VERSION ""

NS_ :

BS_:

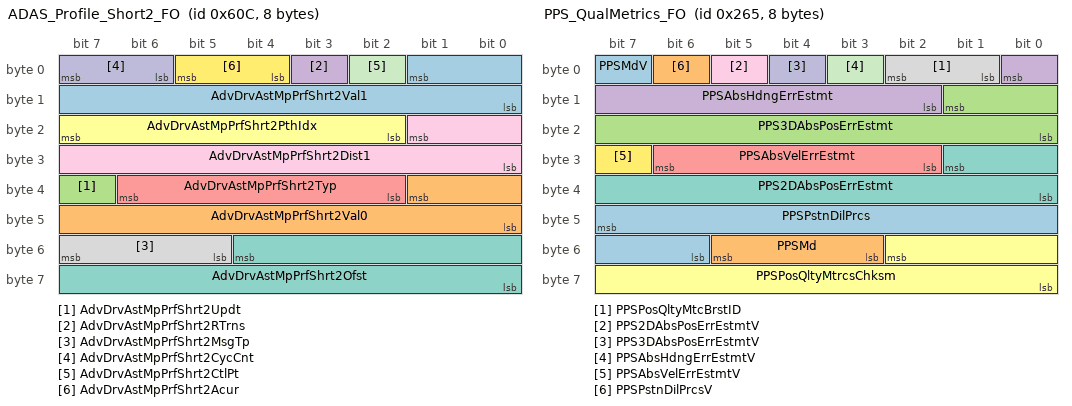
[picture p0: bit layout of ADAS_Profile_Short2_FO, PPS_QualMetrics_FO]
BO_ 1548 ADAS_Profile_Short2_FO: 8 AMM_FO
 SG_ AdvDrvAstMpPrfShrt2Val1 : 1|10@0+ (1,0) [0|1023] ""  EOCM2A_IMX6_FO,EOCM2A_K2_FO,EOCM2A_K1_FO,EOCM2B_IMX6_FO,EOCM2B_K2_FO,EOCM2B_K1_FO
 SG_ AdvDrvAstMpPrfShrt2Val0 : 33|10@0+ (1,0) [0|1023] ""  EOCM2A_IMX6_FO,EOCM2A_K2_FO,EOCM2A_K1_FO,EOCM2B_IMX6_FO,EOCM2B_K2_FO,EOCM2B_K1_FO
 SG_ AdvDrvAstMpPrfShrt2Updt : 39|1@0+ (1,0) [0|1] ""  EOCM2A_IMX6_FO,EOCM2A_K2_FO,EOCM2A_K1_FO,EOCM2B_IMX6_FO,EOCM2B_K2_FO,EOCM2B_K1_FO
 SG_ AdvDrvAstMpPrfShrt2RTrns : 3|1@0+ (1,0) [0|1] ""  EOCM2A_IMX6_FO,EOCM2A_K2_FO,EOCM2A_K1_FO,EOCM2B_IMX6_FO,EOCM2B_K2_FO,EOCM2B_K1_FO
 SG_ AdvDrvAstMpPrfShrt2Typ : 38|5@0+ (1,0) [0|31] ""  EOCM2A_IMX6_FO,EOCM2A_K2_FO,EOCM2A_K1_FO,EOCM2B_IMX6_FO,EOCM2B_K2_FO,EOCM2B_K1_FO
 SG_ AdvDrvAstMpPrfShrt2PthIdx : 23|6@0+ (1,0) [0|63] ""  EOCM2A_IMX6_FO,EOCM2A_K2_FO,EOCM2A_K1_FO,EOCM2B_IMX6_FO,EOCM2B_K2_FO,EOCM2B_K1_FO
 SG_ AdvDrvAstMpPrfShrt2Ofst : 52|13@0+ (1,0) [0|8191] "m"  EOCM2A_IMX6_FO,EOCM2A_K2_FO,EOCM2A_K1_FO,EOCM2B_IMX6_FO,EOCM2B_K2_FO,EOCM2B_K1_FO
 SG_ AdvDrvAstMpPrfShrt2MsgTp : 55|3@0+ (1,0) [0|7] ""  EOCM2A_IMX6_FO,EOCM2A_K2_FO,EOCM2A_K1_FO,EOCM2B_IMX6_FO,EOCM2B_K2_FO,EOCM2B_K1_FO
 SG_ AdvDrvAstMpPrfShrt2Dist1 : 17|10@0+ (1,0) [0|1023] "m"  EOCM2A_IMX6_FO,EOCM2A_K2_FO,EOCM2A_K1_FO,EOCM2B_IMX6_FO,EOCM2B_K2_FO,EOCM2B_K1_FO
 SG_ AdvDrvAstMpPrfShrt2CycCnt : 7|2@0+ (1,0) [0|3] ""  EOCM2A_IMX6_FO,EOCM2A_K2_FO,EOCM2A_K1_FO,EOCM2B_IMX6_FO,EOCM2B_K2_FO,EOCM2B_K1_FO
 SG_ AdvDrvAstMpPrfShrt2CtlPt : 2|1@0+ (1,0) [0|1] ""  EOCM2A_IMX6_FO,EOCM2A_K2_FO,EOCM2A_K1_FO,EOCM2B_IMX6_FO,EOCM2B_K2_FO,EOCM2B_K1_FO
 SG_ AdvDrvAstMpPrfShrt2Acur : 5|2@0+ (1,0) [0|3] ""  EOCM2A_IMX6_FO,EOCM2A_K2_FO,EOCM2A_K1_FO,EOCM2B_IMX6_FO,EOCM2B_K2_FO,EOCM2B_K1_FO

BO_ 1547 ADAS_Profile_Long2_FO: 8 AMM_FO
 SG_ AdvDrAstMpProfLng2Val : 39|32@0+ (1,0) [0|4294967295] ""  EOCM2A_IMX6_FO,EOCM2A_K2_FO,EOCM2A_K1_FO,EOCM2B_IMX6_FO,EOCM2B_K2_FO,EOCM2B_K1_FO
 SG_ AdvDrAstMpPrfLng2Updt : 7|1@0+ (1,0) [0|1] ""  EOCM2A_IMX6_FO,EOCM2A_K2_FO,EOCM2A_K1_FO,EOCM2B_IMX6_FO,EOCM2B_K2_FO,EOCM2B_K1_FO
 SG_ AdvDrAstMpPrfLng2RTrns : 6|1@0+ (1,0) [0|1] ""  EOCM2A_IMX6_FO,EOCM2A_K2_FO,EOCM2A_K1_FO,EOCM2B_IMX6_FO,EOCM2B_K2_FO,EOCM2B_K1_FO
 SG_ AdvDrAstMpPrfLng2PrfTyp : 4|5@0+ (1,0) [0|31] ""  EOCM2A_IMX6_FO,EOCM2A_K2_FO,EOCM2A_K1_FO,EOCM2B_IMX6_FO,EOCM2B_K2_FO,EOCM2B_K1_FO
 SG_ AdvDrAstMpPrfLng2PthIdx : 13|6@0+ (1,0) [0|63] ""  EOCM2A_IMX6_FO,EOCM2A_K2_FO,EOCM2A_K1_FO,EOCM2B_IMX6_FO,EOCM2B_K2_FO,EOCM2B_K1_FO
 SG_ AdvDrAstMpPrfLng2Ofst : 20|13@0+ (1,0) [0|8191] "m"  EOCM2A_IMX6_FO,EOCM2A_K2_FO,EOCM2A_K1_FO,EOCM2B_IMX6_FO,EOCM2B_K2_FO,EOCM2B_K1_FO
 SG_ AdvDrAstMpPrfLng2MgTyp : 23|3@0+ (1,0) [0|7] ""  EOCM2A_IMX6_FO,EOCM2A_K2_FO,EOCM2A_K1_FO,EOCM2B_IMX6_FO,EOCM2B_K2_FO,EOCM2B_K1_FO
 SG_ AdvDrAstMpPrfLng2CycCt : 15|2@0+ (1,0) [0|3] ""  EOCM2A_IMX6_FO,EOCM2A_K2_FO,EOCM2A_K1_FO,EOCM2B_IMX6_FO,EOCM2B_K2_FO,EOCM2B_K1_FO
 SG_ AdvDrAstMpPrfLng2CtrlPt : 5|1@0+ (1,0) [0|1] ""  EOCM2A_IMX6_FO,EOCM2A_K2_FO,EOCM2A_K1_FO,EOCM2B_IMX6_FO,EOCM2B_K2_FO,EOCM2B_K1_FO

BO_ 1630 USDT_Resp_From_EOCM2B_K2_FO: 8 EOCM2B_K2_FO
 SG_ DgnInf : 7|64@0+ (1,0) [0|1.84467440737096E+019] ""  TestTool_FO

BO_ 1374 UUDT_Resp_From_EOCM2B_K2_FO: 8 EOCM2B_K2_FO
 SG_ DgnInf : 7|64@0+ (1,0) [0|1.84467440737096E+019] ""  TestTool_FO

BO_ 606 USDT_Req_to_EOCM2B_K2_FO: 8 TestTool_FO
 SG_ DgnInf : 7|64@0+ (1,0) [0|1.84467440737096E+019] ""  EOCM2B_K2_FO

BO_ 328 Vehicle_Info_FO: 5 EOCM2A_K1_FO
 SG_ StrWhAngGrd : 27|12@0- (1,0) [-2048|2047] "deg/sec"  DMS_FO
 SG_ TrnsShftLvrPos : 31|4@0+ (1,0) [0|15] ""  DMS_FO
 SG_ StrWhAng_148 : 15|16@0- (0.0625,0) [-2048|2047.9375] "deg"  DMS_FO
 SG_ TrnsShftLvrPosV : 3|1@0+ (1,0) [0|1] ""  DMS_FO
 SG_ StrWhAngV_148 : 4|1@0+ (1,0) [0|1] ""  DMS_FO
 SG_ StrWhAngMsk_148 : 5|1@0+ (1,0) [0|1] ""  DMS_FO
 SG_ StrWhAngGrdV : 6|1@0+ (1,0) [0|1] ""  DMS_FO
 SG_ StrWhAngGrdMsk : 7|1@0+ (1,0) [0|1] ""  DMS_FO

BO_ 1930 DTC_Triggered_78A_FO: 7 LRSRR_FO
 SG_ DTCI_CodeSupported_78A : 40|1@0+ (1,0) [0|1] ""  TestTool_FO
 SG_ DTCI_CurrentStatus_78A : 41|1@0+ (1,0) [0|1] ""  TestTool_FO
 SG_ DTCI_DTCFailType_78A : 39|8@0+ (1,0) [0|255] ""  TestTool_FO
 SG_ DTCI_DTCFaultType_78A : 55|8@0+ (1,0) [0|255] ""  TestTool_FO
 SG_ DTCI_DTCNumber_78A : 23|16@0+ (1,0) [0|65535] ""  TestTool_FO
 SG_ DTCI_DTCSource_78A : 15|8@0+ (1,0) [0|255] ""  TestTool_FO
 SG_ DTCI_DTCTriggered_78A : 0|1@0+ (1,0) [0|1] ""  TestTool_FO
 SG_ DTCI_HistStat_78A : 44|1@0+ (1,0) [0|1] ""  TestTool_FO
 SG_ DTCI_TstFldCdClrdStat_78A : 43|1@0+ (1,0) [0|1] ""  TestTool_FO
 SG_ DTCI_TstFldPwrUpSt_78A : 46|1@0+ (1,0) [0|1] ""  TestTool_FO
 SG_ DTCI_TstNPsdCdClrdSt_78A : 42|1@0+ (1,0) [0|1] ""  TestTool_FO
 SG_ DTCI_TstNPsdPwrUpSt_78A : 45|1@0+ (1,0) [0|1] ""  TestTool_FO
 SG_ DTCIUnused1_78A : 7|1@0+ (1,0) [0|1] ""  TestTool_FO
 SG_ DTCIUnused2_78A : 6|1@0+ (1,0) [0|1] ""  TestTool_FO
 SG_ DTCIUnused3_78A : 5|1@0+ (1,0) [0|1] ""  TestTool_FO
 SG_ DTCIUnused4_78A : 4|1@0+ (1,0) [0|1] ""  TestTool_FO
 SG_ DTCIUnused5_78A : 3|1@0+ (1,0) [0|1] ""  TestTool_FO
 SG_ DTCIUnused6_78A : 2|1@0+ (1,0) [0|1] ""  TestTool_FO
 SG_ DTCIUnused7_78A : 1|1@0+ (1,0) [0|1] ""  TestTool_FO
 SG_ DTCI_WrnIndRqdSt_78A : 47|1@0+ (1,0) [0|1] ""  TestTool_FO

BO_ 1624 USDT_Resp_From_LRSRR: 8 LRSRR_FO
 SG_ DgnInf : 7|64@0+ (1,0) [0|1.84467440737096E+019] ""  TestTool_FO

BO_ 1368 UUDT_Resp_From_LRSRR: 8 LRSRR_FO
 SG_ DgnInf : 7|64@0+ (1,0) [0|1.84467440737096E+019] ""  TestTool_FO

BO_ 600 USDT_Req_to_LRSRR: 8 TestTool_FO
 SG_ DgnInf : 7|64@0+ (1,0) [0|1.84467440737096E+019] ""  LRSRR_FO

BO_ 613 PPS_QualMetrics_FO: 8 EOCM2A_K1_FO
 SG_ PPSPstnDilPrcs : 47|10@0+ (0.1,0) [0|102.3] ""  EOCM2B_IMX6_FO,EOCM2B_K2_FO,EOCM2B_K1_FO,AMM_FO
 SG_ PPSMd : 53|3@0+ (1,0) [0|7] ""  EOCM2B_IMX6_FO,EOCM2B_K2_FO,EOCM2B_K1_FO,AMM_FO
 SG_ PPS3DAbsPosErrEstmt : 9|10@0+ (0.1,0) [0|102.3] ""  EOCM2B_IMX6_FO,EOCM2B_K2_FO,EOCM2B_K1_FO,AMM_FO
 SG_ PPSAbsHdngErrEstmt : 0|7@0+ (0.5,0) [0|63.5] ""  EOCM2B_IMX6_FO,EOCM2B_K2_FO,EOCM2B_K1_FO,AMM_FO
 SG_ PPSAbsVelErrEstmt : 30|5@0+ (1,0) [0|31] ""  EOCM2B_IMX6_FO,EOCM2B_K2_FO,EOCM2B_K1_FO,AMM_FO
 SG_ PPSPosQltyMtrcsChksm : 50|11@0+ (1,0) [0|2047] ""  EOCM2B_IMX6_FO,EOCM2B_K2_FO,EOCM2B_K1_FO,AMM_FO
 SG_ PPS2DAbsPosErrEstmt : 25|10@0+ (0.1,0) [0|102.3] ""  EOCM2B_IMX6_FO,EOCM2B_K2_FO,EOCM2B_K1_FO,AMM_FO
 SG_ PPSPosQltyMtcBrstID : 2|2@0+ (1,0) [0|3] ""  EOCM2B_IMX6_FO,EOCM2B_K2_FO,EOCM2B_K1_FO,AMM_FO
 SG_ PPS2DAbsPosErrEstmtV : 5|1@0+ (1,0) [0|1] ""  EOCM2B_IMX6_FO,EOCM2B_K2_FO,EOCM2B_K1_FO,AMM_FO
 SG_ PPS3DAbsPosErrEstmtV : 4|1@0+ (1,0) [0|1] ""  EOCM2B_IMX6_FO,EOCM2B_K2_FO,EOCM2B_K1_FO,AMM_FO
 SG_ PPSAbsHdngErrEstmtV : 3|1@0+ (1,0) [0|1] ""  EOCM2B_IMX6_FO,EOCM2B_K2_FO,EOCM2B_K1_FO,AMM_FO
 SG_ PPSAbsVelErrEstmtV : 31|1@0+ (1,0) [0|1] ""  EOCM2B_IMX6_FO,EOCM2B_K2_FO,EOCM2B_K1_FO,AMM_FO
 SG_ PPSMdV : 7|1@0+ (1,0) [0|1] ""  EOCM2B_IMX6_FO,EOCM2B_K2_FO,EOCM2B_K1_FO,AMM_FO
 SG_ PPSPstnDilPrcsV : 6|1@0+ (1,0) [0|1] ""  EOCM2B_IMX6_FO,EOCM2B_K2_FO,EOCM2B_K1_FO,AMM_FO

BO_ 612 PPS_Time_FO: 8 EOCM2A_K1_FO
 SG_ PPSTmdayV : 2|1@0+ (1,0) [0|1] ""  EOCM2B_IMX6_FO,EOCM2B_K2_FO,EOCM2B_K1_FO,AMM_FO
 SG_ PPSCldrDayV : 0|1@0+ (1,0) [0|1] ""  EOCM2B_IMX6_FO,EOCM2B_K2_FO,EOCM2B_K1_FO,AMM_FO
 SG_ PPSCldrDay : 8|9@0+ (1,0) [0|511] ""  EOCM2B_IMX6_FO,EOCM2B_K2_FO,EOCM2B_K1_FO,AMM_FO
 SG_ PPSTmBrstID : 52|2@0+ (1,0) [0|3] ""  EOCM2B_IMX6_FO,EOCM2B_K2_FO,EOCM2B_K1_FO,AMM_FO
 SG_ PPSTmday : 31|27@0+ (1,0) [0|134217727] "ms"  EOCM2B_IMX6_FO,EOCM2B_K2_FO,EOCM2B_K1_FO,AMM_FO
 SG_ PPSTmChksm : 50|11@0+ (1,0) [0|2047] ""  EOCM2B_IMX6_FO,EOCM2B_K2_FO,EOCM2B_K1_FO,AMM_FO
 SG_ PPSCldrYrV : 1|1@0+ (1,0) [0|1] ""  EOCM2B_IMX6_FO,EOCM2B_K2_FO,EOCM2B_K1_FO,AMM_FO
 SG_ PPSCldrYr : 15|7@0+ (1,2014) [2014|2141] ""  EOCM2B_IMX6_FO,EOCM2B_K2_FO,EOCM2B_K1_FO,AMM_FO

BO_ 611 PPS_SigAcqTime_FO: 6 EOCM2A_K1_FO
 SG_ PPSSigAqTmBrstID : 38|2@0+ (1,0) [0|3] ""  EOCM2B_IMX6_FO,EOCM2B_K2_FO,EOCM2B_K1_FO,AMM_FO
 SG_ PPSSigAcqTmV : 39|1@0+ (1,0) [0|1] ""  EOCM2B_IMX6_FO,EOCM2B_K2_FO,EOCM2B_K1_FO,AMM_FO
 SG_ PPSSigAcqTm : 7|32@0+ (1,0) [0|4294967295] ""  EOCM2B_IMX6_FO,EOCM2B_K2_FO,EOCM2B_K1_FO,AMM_FO
 SG_ PPSSigAqTmChksm : 34|11@0+ (1,0) [0|2047] ""  EOCM2B_IMX6_FO,EOCM2B_K2_FO,EOCM2B_K1_FO,AMM_FO

BO_ 610 PPS_PosLong_FO: 6 EOCM2A_K1_FO
 SG_ PPSLongBrstID : 39|2@0+ (1,0) [0|3] ""  EOCM2B_IMX6_FO,EOCM2B_K2_FO,EOCM2B_K1_FO,AMM_FO
 SG_ PPSLong : 6|31@0- (1,0) [-1073741824|1073741823] ""  EOCM2B_IMX6_FO,EOCM2B_K2_FO,EOCM2B_K1_FO,AMM_FO
 SG_ PPSLongV : 7|1@0+ (1,0) [0|1] ""  EOCM2B_IMX6_FO,EOCM2B_K2_FO,EOCM2B_K1_FO,AMM_FO
 SG_ PPSLongChksm : 34|11@0+ (1,0) [0|2047] ""  EOCM2B_IMX6_FO,EOCM2B_K2_FO,EOCM2B_K1_FO,AMM_FO

BO_ 609 PPS_PosLat_FO: 6 EOCM2A_K1_FO
 SG_ PPSLatV : 7|1@0+ (1,0) [0|1] ""  EOCM2B_IMX6_FO,EOCM2B_K2_FO,EOCM2B_K1_FO,AMM_FO
 SG_ PPSLatChksm : 34|11@0+ (1,0) [0|2047] ""  EOCM2B_IMX6_FO,EOCM2B_K2_FO,EOCM2B_K1_FO,AMM_FO
 SG_ PPSLatBrstID : 36|2@0+ (1,0) [0|3] ""  EOCM2B_IMX6_FO,EOCM2B_K2_FO,EOCM2B_K1_FO,AMM_FO
 SG_ PPSLat : 5|30@0- (1,0) [-536870912|536870911] ""  EOCM2B_IMX6_FO,EOCM2B_K2_FO,EOCM2B_K1_FO,AMM_FO

BO_ 1160 PassPhrase_3_AMM_FO: 8 EOCM2A_K1_FO
 SG_ WiFiPssPhrsDgts17to24_Mp : 7|64@0+ (1,0) [0|0] ""  EOCM2B_K1_FO,AMM_FO

BO_ 1159 PassPhrase_2_AMM_FO: 8 EOCM2A_K1_FO
 SG_ WiFiPssPhrsDgts9to16_Mp : 7|64@0+ (1,0) [0|0] ""  EOCM2B_K1_FO,AMM_FO

BO_ 1158 PassPhrase_1_AMM_FO: 8 EOCM2A_K1_FO
 SG_ WiFiPssPhrsDgts1to8_Mp : 7|64@0+ (1,0) [0|0] ""  EOCM2B_K1_FO,AMM_FO

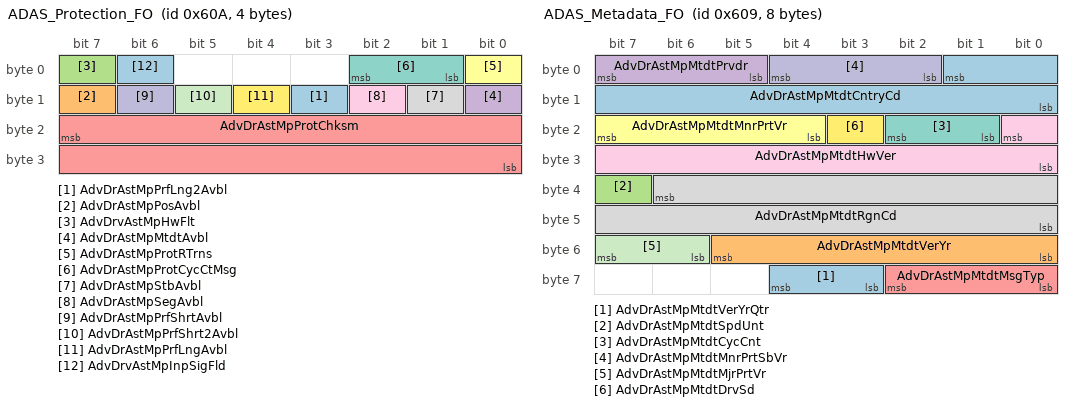
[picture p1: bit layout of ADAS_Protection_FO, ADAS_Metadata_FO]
BO_ 1546 ADAS_Protection_FO: 4 AMM_FO
 SG_ AdvDrAstMpPrfLng2Avbl : 11|1@0+ (1,0) [0|1] ""  EOCM2A_IMX6_FO,EOCM2A_K2_FO,EOCM2A_K1_FO,EOCM2B_IMX6_FO,EOCM2B_K2_FO,EOCM2B_K1_FO
 SG_ AdvDrAstMpPosAvbl : 15|1@0+ (1,0) [0|1] ""  EOCM2A_IMX6_FO,EOCM2A_K2_FO,EOCM2A_K1_FO,EOCM2B_IMX6_FO,EOCM2B_K2_FO,EOCM2B_K1_FO
 SG_ AdvDrvAstMpHwFlt : 7|1@0+ (1,0) [0|1] ""  EOCM2B_IMX6_FO,EOCM2B_K2_FO,EOCM2B_K1_FO,EOCM2A_IMX6_FO,EOCM2A_K2_FO,EOCM2A_K1_FO
 SG_ AdvDrAstMpMtdtAvbl : 8|1@0+ (1,0) [0|1] ""  EOCM2A_IMX6_FO,EOCM2A_K2_FO,EOCM2A_K1_FO,EOCM2B_IMX6_FO,EOCM2B_K2_FO,EOCM2B_K1_FO
 SG_ AdvDrAstMpProtChksm : 23|16@0+ (1,0) [0|65535] ""  EOCM2A_IMX6_FO,EOCM2A_K2_FO,EOCM2A_K1_FO,EOCM2B_IMX6_FO,EOCM2B_K2_FO,EOCM2B_K1_FO
 SG_ AdvDrAstMpProtRTrns : 0|1@0+ (1,0) [0|1] ""  EOCM2B_IMX6_FO,EOCM2B_K2_FO,EOCM2B_K1_FO,EOCM2A_IMX6_FO,EOCM2A_K2_FO,EOCM2A_K1_FO
 SG_ AdvDrAstMpProtCycCtMsg : 2|2@0+ (1,0) [0|3] ""  EOCM2B_IMX6_FO,EOCM2B_K2_FO,EOCM2B_K1_FO,EOCM2A_IMX6_FO,EOCM2A_K2_FO,EOCM2A_K1_FO
 SG_ AdvDrAstMpStbAvbl : 9|1@0+ (1,0) [0|1] ""  EOCM2A_IMX6_FO,EOCM2A_K2_FO,EOCM2A_K1_FO,EOCM2B_IMX6_FO,EOCM2B_K2_FO,EOCM2B_K1_FO
 SG_ AdvDrAstMpSegAvbl : 10|1@0+ (1,0) [0|1] ""  EOCM2A_IMX6_FO,EOCM2A_K2_FO,EOCM2A_K1_FO,EOCM2B_IMX6_FO,EOCM2B_K2_FO,EOCM2B_K1_FO
 SG_ AdvDrAstMpPrfShrtAvbl : 14|1@0+ (1,0) [0|1] ""  EOCM2A_IMX6_FO,EOCM2A_K2_FO,EOCM2A_K1_FO,EOCM2B_IMX6_FO,EOCM2B_K2_FO,EOCM2B_K1_FO
 SG_ AdvDrAstMpPrfShrt2Avbl : 13|1@0+ (1,0) [0|1] ""  EOCM2A_IMX6_FO,EOCM2A_K2_FO,EOCM2A_K1_FO,EOCM2B_IMX6_FO,EOCM2B_K2_FO,EOCM2B_K1_FO
 SG_ AdvDrAstMpPrfLngAvbl : 12|1@0+ (1,0) [0|1] ""  EOCM2A_IMX6_FO,EOCM2A_K2_FO,EOCM2A_K1_FO,EOCM2B_IMX6_FO,EOCM2B_K2_FO,EOCM2B_K1_FO
 SG_ AdvDrvAstMpInpSigFld : 6|1@0+ (1,0) [0|1] ""  EOCM2B_IMX6_FO,EOCM2B_K2_FO,EOCM2B_K1_FO,EOCM2A_IMX6_FO,EOCM2A_K2_FO,EOCM2A_K1_FO

BO_ 1545 ADAS_Metadata_FO: 8 AMM_FO
 SG_ AdvDrAstMpMtdtVerYrQtr : 60|2@0+ (1,1) [1|4] "Qtr"  EOCM2B_IMX6_FO,EOCM2B_K2_FO,EOCM2B_K1_FO,EOCM2A_IMX6_FO,EOCM2A_K2_FO,EOCM2A_K1_FO
 SG_ AdvDrAstMpMtdtVerYr : 53|6@0+ (1,2000) [2000|2063] "Year"  EOCM2B_IMX6_FO,EOCM2B_K2_FO,EOCM2B_K1_FO,EOCM2A_IMX6_FO,EOCM2A_K2_FO,EOCM2A_K1_FO
 SG_ AdvDrAstMpMtdtSpdUnt : 39|1@0+ (1,0) [0|1] ""  EOCM2B_IMX6_FO,EOCM2B_K2_FO,EOCM2B_K1_FO,EOCM2A_IMX6_FO,EOCM2A_K2_FO,EOCM2A_K1_FO
 SG_ AdvDrAstMpMtdtPrvdr : 7|3@0+ (1,0) [0|7] ""  EOCM2B_IMX6_FO,EOCM2B_K2_FO,EOCM2B_K1_FO,EOCM2A_IMX6_FO,EOCM2A_K2_FO,EOCM2A_K1_FO
 SG_ AdvDrAstMpMtdtMsgTyp : 58|3@0+ (1,0) [0|7] ""  EOCM2B_IMX6_FO,EOCM2B_K2_FO,EOCM2B_K1_FO,EOCM2A_IMX6_FO,EOCM2A_K2_FO,EOCM2A_K1_FO
 SG_ AdvDrAstMpMtdtMnrPrtVr : 23|4@0+ (1,0) [0|15] ""  EOCM2B_IMX6_FO,EOCM2B_K2_FO,EOCM2B_K1_FO,EOCM2A_IMX6_FO,EOCM2A_K2_FO,EOCM2A_K1_FO
 SG_ AdvDrAstMpMtdtCycCnt : 18|2@0+ (1,0) [0|3] ""  EOCM2B_IMX6_FO,EOCM2B_K2_FO,EOCM2B_K1_FO,EOCM2A_IMX6_FO,EOCM2A_K2_FO,EOCM2A_K1_FO
 SG_ AdvDrAstMpMtdtRgnCd : 38|15@0+ (1,0) [0|32767] ""  EOCM2B_IMX6_FO,EOCM2B_K2_FO,EOCM2B_K1_FO,EOCM2A_IMX6_FO,EOCM2A_K2_FO,EOCM2A_K1_FO
 SG_ AdvDrAstMpMtdtHwVer : 16|9@0+ (1,0) [0|511] ""  EOCM2B_IMX6_FO,EOCM2B_K2_FO,EOCM2B_K1_FO,EOCM2A_IMX6_FO,EOCM2A_K2_FO,EOCM2A_K1_FO
 SG_ AdvDrAstMpMtdtMnrPrtSbVr : 4|3@0+ (1,0) [0|7] ""  EOCM2B_IMX6_FO,EOCM2B_K2_FO,EOCM2B_K1_FO,EOCM2A_IMX6_FO,EOCM2A_K2_FO,EOCM2A_K1_FO
 SG_ AdvDrAstMpMtdtMjrPrtVr : 55|2@0+ (1,0) [0|3] ""  EOCM2B_IMX6_FO,EOCM2B_K2_FO,EOCM2B_K1_FO,EOCM2A_IMX6_FO,EOCM2A_K2_FO,EOCM2A_K1_FO
 SG_ AdvDrAstMpMtdtDrvSd : 19|1@0+ (1,0) [0|1] ""  EOCM2B_IMX6_FO,EOCM2B_K2_FO,EOCM2B_K1_FO,EOCM2A_IMX6_FO,EOCM2A_K2_FO,EOCM2A_K1_FO
 SG_ AdvDrAstMpMtdtCntryCd : 1|10@0+ (1,0) [0|1023] ""  EOCM2B_IMX6_FO,EOCM2B_K2_FO,EOCM2B_K1_FO,EOCM2A_IMX6_FO,EOCM2A_K2_FO,EOCM2A_K1_FO

BO_ 1543 ADAS_Profile_Long_FO: 8 AMM_FO
 SG_ AdvDrAstMpPrfLngUpdt : 7|1@0+ (1,0) [0|1] ""  EOCM2B_IMX6_FO,EOCM2B_K2_FO,EOCM2B_K1_FO,EOCM2A_IMX6_FO,EOCM2A_K2_FO,EOCM2A_K1_FO
 SG_ AdvDrAstMpPrfLngRTrns : 6|1@0+ (1,0) [0|1] ""  EOCM2B_IMX6_FO,EOCM2B_K2_FO,EOCM2B_K1_FO,EOCM2A_IMX6_FO,EOCM2A_K2_FO,EOCM2A_K1_FO
 SG_ AdvDrAstMpPrfLngCtlPt : 5|1@0+ (1,0) [0|1] ""  EOCM2B_IMX6_FO,EOCM2B_K2_FO,EOCM2B_K1_FO,EOCM2A_IMX6_FO,EOCM2A_K2_FO,EOCM2A_K1_FO
 SG_ AdvDrAstMpPrfLngTyp : 4|5@0+ (1,0) [0|31] ""  EOCM2B_IMX6_FO,EOCM2B_K2_FO,EOCM2B_K1_FO,EOCM2A_IMX6_FO,EOCM2A_K2_FO,EOCM2A_K1_FO
 SG_ AdvDrAstMpPrfLngCycCt : 15|2@0+ (1,0) [0|3] ""  EOCM2B_IMX6_FO,EOCM2B_K2_FO,EOCM2B_K1_FO,EOCM2A_IMX6_FO,EOCM2A_K2_FO,EOCM2A_K1_FO
 SG_ AdvDrAstMpPrfLngPthIdx : 13|6@0+ (1,0) [0|63] ""  EOCM2B_IMX6_FO,EOCM2B_K2_FO,EOCM2B_K1_FO,EOCM2A_IMX6_FO,EOCM2A_K2_FO,EOCM2A_K1_FO
 SG_ AdvDrAstMpPrfLngMsgTp : 23|3@0+ (1,0) [0|7] ""  EOCM2B_IMX6_FO,EOCM2B_K2_FO,EOCM2B_K1_FO,EOCM2A_IMX6_FO,EOCM2A_K2_FO,EOCM2A_K1_FO
 SG_ AdvDrAstMpPrfLngOfst : 20|13@0+ (1,0) [0|8191] "m"  EOCM2B_IMX6_FO,EOCM2B_K2_FO,EOCM2B_K1_FO,EOCM2A_IMX6_FO,EOCM2A_K2_FO,EOCM2A_K1_FO
 SG_ AdvDrAstMpPrfLngVal : 39|32@0+ (1,0) [0|4294967295] ""  EOCM2B_IMX6_FO,EOCM2B_K2_FO,EOCM2B_K1_FO,EOCM2A_IMX6_FO,EOCM2A_K2_FO,EOCM2A_K1_FO

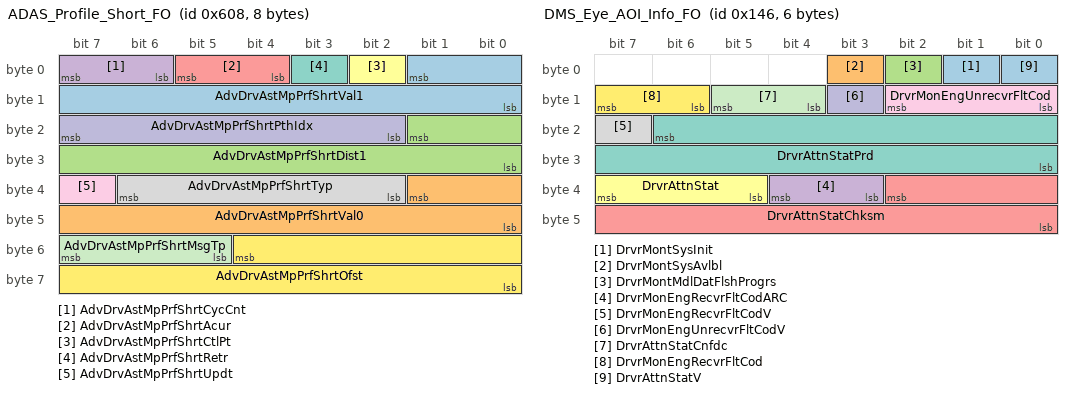
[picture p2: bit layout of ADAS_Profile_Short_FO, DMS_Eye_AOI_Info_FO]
BO_ 1544 ADAS_Profile_Short_FO: 8 AMM_FO
 SG_ AdvDrvAstMpPrfShrtVal1 : 1|10@0+ (1,0) [0|1023] ""  EOCM2B_IMX6_FO,EOCM2B_K2_FO,EOCM2B_K1_FO,EOCM2A_IMX6_FO,EOCM2A_K2_FO,EOCM2A_K1_FO
 SG_ AdvDrvAstMpPrfShrtVal0 : 33|10@0+ (1,0) [0|1023] ""  EOCM2B_IMX6_FO,EOCM2B_K2_FO,EOCM2B_K1_FO,EOCM2A_IMX6_FO,EOCM2A_K2_FO,EOCM2A_K1_FO
 SG_ AdvDrvAstMpPrfShrtDist1 : 17|10@0+ (1,0) [0|1023] "m"  EOCM2B_IMX6_FO,EOCM2B_K2_FO,EOCM2B_K1_FO,EOCM2A_IMX6_FO,EOCM2A_K2_FO,EOCM2A_K1_FO
 SG_ AdvDrvAstMpPrfShrtCycCnt : 7|2@0+ (1,0) [0|3] ""  EOCM2B_IMX6_FO,EOCM2B_K2_FO,EOCM2B_K1_FO,EOCM2A_IMX6_FO,EOCM2A_K2_FO,EOCM2A_K1_FO
 SG_ AdvDrvAstMpPrfShrtAcur : 5|2@0+ (1,0) [0|3] ""  EOCM2B_IMX6_FO,EOCM2B_K2_FO,EOCM2B_K1_FO,EOCM2A_IMX6_FO,EOCM2A_K2_FO,EOCM2A_K1_FO
 SG_ AdvDrvAstMpPrfShrtCtlPt : 2|1@0+ (1,0) [0|1] ""  EOCM2B_IMX6_FO,EOCM2B_K2_FO,EOCM2B_K1_FO,EOCM2A_IMX6_FO,EOCM2A_K2_FO,EOCM2A_K1_FO
 SG_ AdvDrvAstMpPrfShrtRetr : 3|1@0+ (1,0) [0|1] ""  EOCM2B_IMX6_FO,EOCM2B_K2_FO,EOCM2B_K1_FO,EOCM2A_IMX6_FO,EOCM2A_K2_FO,EOCM2A_K1_FO
 SG_ AdvDrvAstMpPrfShrtTyp : 38|5@0+ (1,0) [0|31] ""  EOCM2B_IMX6_FO,EOCM2B_K2_FO,EOCM2B_K1_FO,EOCM2A_IMX6_FO,EOCM2A_K2_FO,EOCM2A_K1_FO
 SG_ AdvDrvAstMpPrfShrtUpdt : 39|1@0+ (1,0) [0|1] ""  EOCM2B_IMX6_FO,EOCM2B_K2_FO,EOCM2B_K1_FO,EOCM2A_IMX6_FO,EOCM2A_K2_FO,EOCM2A_K1_FO
 SG_ AdvDrvAstMpPrfShrtPthIdx : 23|6@0+ (1,0) [0|63] ""  EOCM2B_IMX6_FO,EOCM2B_K2_FO,EOCM2B_K1_FO,EOCM2A_IMX6_FO,EOCM2A_K2_FO,EOCM2A_K1_FO
 SG_ AdvDrvAstMpPrfShrtMsgTp : 55|3@0+ (1,0) [0|7] ""  EOCM2B_IMX6_FO,EOCM2B_K2_FO,EOCM2B_K1_FO,EOCM2A_IMX6_FO,EOCM2A_K2_FO,EOCM2A_K1_FO
 SG_ AdvDrvAstMpPrfShrtOfst : 52|13@0+ (1,0) [0|8191] "m"  EOCM2B_IMX6_FO,EOCM2B_K2_FO,EOCM2B_K1_FO,EOCM2A_IMX6_FO,EOCM2A_K2_FO,EOCM2A_K1_FO

BO_ 1542 ADAS_Stub_FO: 8 AMM_FO
 SG_ AdvDrAstMpStbSubPthIdx : 63|6@0+ (1,0) [0|63] ""  EOCM2B_IMX6_FO,EOCM2B_K2_FO,EOCM2B_K1_FO,EOCM2A_IMX6_FO,EOCM2A_K2_FO,EOCM2A_K1_FO
 SG_ AdvDrAstMpStbUpdt : 55|1@0+ (1,0) [0|1] ""  EOCM2B_IMX6_FO,EOCM2B_K2_FO,EOCM2B_K1_FO,EOCM2A_IMX6_FO,EOCM2A_K2_FO,EOCM2A_K1_FO
 SG_ AdvDrAstMpStbPrtCalRut : 57|2@0+ (1,0) [0|3] ""  EOCM2B_IMX6_FO,EOCM2B_K2_FO,EOCM2B_K1_FO,EOCM2A_IMX6_FO,EOCM2A_K2_FO,EOCM2A_K1_FO
 SG_ AdvDrAstMpStbNmLnDrvDir : 54|3@0+ (1,0) [0|7] ""  EOCM2B_IMX6_FO,EOCM2B_K2_FO,EOCM2B_K1_FO,EOCM2A_IMX6_FO,EOCM2A_K2_FO,EOCM2A_K1_FO
 SG_ AdvDrAstMpStbCycCnt : 51|2@0+ (1,0) [0|3] ""  EOCM2B_IMX6_FO,EOCM2B_K2_FO,EOCM2B_K1_FO,EOCM2A_IMX6_FO,EOCM2A_K2_FO,EOCM2A_K1_FO
 SG_ AdvDrAstMpStbCmplxInsct : 49|2@0+ (1,0) [0|3] ""  EOCM2B_IMX6_FO,EOCM2B_K2_FO,EOCM2B_K1_FO,EOCM2A_IMX6_FO,EOCM2A_K2_FO,EOCM2A_K1_FO
 SG_ AdvDrAstMpStbTrnAngl : 47|8@0+ (1.417,0) [0|361.335] "deg"  EOCM2B_IMX6_FO,EOCM2B_K2_FO,EOCM2B_K1_FO,EOCM2A_IMX6_FO,EOCM2A_K2_FO,EOCM2A_K1_FO
 SG_ AdvDrAstMpStbRtOfWay : 38|2@0+ (1,0) [0|3] ""  EOCM2B_IMX6_FO,EOCM2B_K2_FO,EOCM2B_K1_FO,EOCM2A_IMX6_FO,EOCM2A_K2_FO,EOCM2A_K1_FO
 SG_ AdvDrAstMpStbRelProb : 36|5@0+ (3.333,0) [0|103.323] "%"  EOCM2B_IMX6_FO,EOCM2B_K2_FO,EOCM2B_K1_FO,EOCM2A_IMX6_FO,EOCM2A_K2_FO,EOCM2A_K1_FO
 SG_ AdvDrAstMpStbRetr : 39|1@0+ (1,0) [0|1] ""  EOCM2B_IMX6_FO,EOCM2B_K2_FO,EOCM2B_K1_FO,EOCM2A_IMX6_FO,EOCM2A_K2_FO,EOCM2A_K1_FO
 SG_ AdvDrAstMpStbNmLnOppDir : 31|2@0+ (1,0) [0|3] ""  EOCM2B_IMX6_FO,EOCM2B_K2_FO,EOCM2B_K1_FO,EOCM2A_IMX6_FO,EOCM2A_K2_FO,EOCM2A_K1_FO
 SG_ AdvDrAstMpStbPathIdx : 29|6@0+ (1,0) [0|63] ""  EOCM2B_IMX6_FO,EOCM2B_K2_FO,EOCM2B_K1_FO,EOCM2A_IMX6_FO,EOCM2A_K2_FO,EOCM2A_K1_FO
 SG_ AdvDrAstMpStbLstStbOfst : 23|1@0+ (1,0) [0|1] ""  EOCM2B_IMX6_FO,EOCM2B_K2_FO,EOCM2B_K1_FO,EOCM2A_IMX6_FO,EOCM2A_K2_FO,EOCM2A_K1_FO
 SG_ AdvDrAstMpStbMsgTyp : 22|3@0+ (1,0) [0|7] ""  EOCM2B_IMX6_FO,EOCM2B_K2_FO,EOCM2B_K1_FO,EOCM2A_IMX6_FO,EOCM2A_K2_FO,EOCM2A_K1_FO
 SG_ AdvDrAstMpStbFmOfWay : 19|4@0+ (1,0) [0|15] ""  EOCM2B_IMX6_FO,EOCM2B_K2_FO,EOCM2B_K1_FO,EOCM2A_IMX6_FO,EOCM2A_K2_FO,EOCM2A_K1_FO
 SG_ AdvDrAstMpStbFuncRdCls : 7|3@0+ (1,0) [0|7] ""  EOCM2B_IMX6_FO,EOCM2B_K2_FO,EOCM2B_K1_FO,EOCM2A_IMX6_FO,EOCM2A_K2_FO,EOCM2A_K1_FO
 SG_ AdvDrAstMpStbOfst : 4|13@0+ (1,0) [0|8191] "m"  EOCM2B_IMX6_FO,EOCM2B_K2_FO,EOCM2B_K1_FO,EOCM2A_IMX6_FO,EOCM2A_K2_FO,EOCM2A_K1_FO

BO_ 1541 ADAS_Segment_FO: 8 AMM_FO
 SG_ AdvDrAstMpSegRelProb : 12|5@0+ (3.333,0) [0|103.323] "%"  EOCM2B_IMX6_FO,EOCM2B_K2_FO,EOCM2B_K1_FO,EOCM2A_IMX6_FO,EOCM2A_K2_FO,EOCM2A_K1_FO
 SG_ AdvDrAstMpSegUpdt : 0|1@0+ (1,0) [0|1] ""  EOCM2B_IMX6_FO,EOCM2B_K2_FO,EOCM2B_K1_FO,EOCM2A_IMX6_FO,EOCM2A_K2_FO,EOCM2A_K1_FO
 SG_ AdvDrAstMpSegTunl : 25|2@0+ (1,0) [0|3] ""  EOCM2B_IMX6_FO,EOCM2B_K2_FO,EOCM2B_K1_FO,EOCM2A_IMX6_FO,EOCM2A_K2_FO,EOCM2A_K1_FO
 SG_ AdvDrAstMpSegCycCnt : 39|2@0+ (1,0) [0|3] ""  EOCM2B_IMX6_FO,EOCM2B_K2_FO,EOCM2B_K1_FO,EOCM2A_IMX6_FO,EOCM2A_K2_FO,EOCM2A_K1_FO
 SG_ AdvDrAstMpSegCmplxInsct : 37|2@0+ (1,0) [0|3] ""  EOCM2B_IMX6_FO,EOCM2B_K2_FO,EOCM2B_K1_FO,EOCM2A_IMX6_FO,EOCM2A_K2_FO,EOCM2A_K1_FO
 SG_ AdvDrAstMpSegBldUpAra : 43|2@0+ (1,0) [0|3] ""  EOCM2B_IMX6_FO,EOCM2B_K2_FO,EOCM2B_K1_FO,EOCM2A_IMX6_FO,EOCM2A_K2_FO,EOCM2A_K1_FO
 SG_ AdvDrAstMpSegBrdg : 41|2@0+ (1,0) [0|3] ""  EOCM2B_IMX6_FO,EOCM2B_K2_FO,EOCM2B_K1_FO,EOCM2A_IMX6_FO,EOCM2A_K2_FO,EOCM2A_K1_FO
 SG_ AdvDrAstMpSegRTrns : 1|1@0+ (1,0) [0|1] ""  EOCM2B_IMX6_FO,EOCM2B_K2_FO,EOCM2B_K1_FO,EOCM2A_IMX6_FO,EOCM2A_K2_FO,EOCM2A_K1_FO
 SG_ AdvDrAstMpSegDivdRd : 31|2@0+ (1,0) [0|3] ""  EOCM2B_IMX6_FO,EOCM2B_K2_FO,EOCM2B_K1_FO,EOCM2A_IMX6_FO,EOCM2A_K2_FO,EOCM2A_K1_FO
 SG_ AdvDrAstMpSegPthIdx : 7|6@0+ (1,0) [0|63] ""  EOCM2B_IMX6_FO,EOCM2B_K2_FO,EOCM2B_K1_FO,EOCM2A_IMX6_FO,EOCM2A_K2_FO,EOCM2A_K1_FO
 SG_ AdvDrAstMpSegPrtCalRut : 27|2@0+ (1,0) [0|3] ""  EOCM2B_IMX6_FO,EOCM2B_K2_FO,EOCM2B_K1_FO,EOCM2A_IMX6_FO,EOCM2A_K2_FO,EOCM2A_K1_FO
 SG_ AdvDrAstMpSegNmLnOppDir : 29|2@0+ (1,0) [0|3] ""  EOCM2B_IMX6_FO,EOCM2B_K2_FO,EOCM2B_K1_FO,EOCM2A_IMX6_FO,EOCM2A_K2_FO,EOCM2A_K1_FO
 SG_ AdvDrAstMpSegNmLnDrvDir : 55|3@0+ (1,0) [0|7] ""  EOCM2B_IMX6_FO,EOCM2B_K2_FO,EOCM2B_K1_FO,EOCM2A_IMX6_FO,EOCM2A_K2_FO,EOCM2A_K1_FO
 SG_ AdvDrAstMpSegMsgTyp : 46|3@0+ (1,0) [0|7] ""  EOCM2B_IMX6_FO,EOCM2B_K2_FO,EOCM2B_K1_FO,EOCM2A_IMX6_FO,EOCM2A_K2_FO,EOCM2A_K1_FO
 SG_ AdvDrAstMpSegFunRdCls : 23|3@0+ (1,0) [0|7] ""  EOCM2B_IMX6_FO,EOCM2B_K2_FO,EOCM2B_K1_FO,EOCM2A_IMX6_FO,EOCM2A_K2_FO,EOCM2A_K1_FO
 SG_ AdvDrAstMpSegFrmOfWay : 35|4@0+ (1,0) [0|15] ""  EOCM2B_IMX6_FO,EOCM2B_K2_FO,EOCM2B_K1_FO,EOCM2A_IMX6_FO,EOCM2A_K2_FO,EOCM2A_K1_FO
 SG_ AdvDrAstMpSegEffSpdLmt : 20|5@0+ (1,0) [0|31] ""  EOCM2B_IMX6_FO,EOCM2B_K2_FO,EOCM2B_K1_FO,EOCM2A_IMX6_FO,EOCM2A_K2_FO,EOCM2A_K1_FO
 SG_ AdvDrAstMpSegEffSdLmtTp : 15|3@0+ (1,0) [0|7] ""  EOCM2B_IMX6_FO,EOCM2B_K2_FO,EOCM2B_K1_FO,EOCM2A_IMX6_FO,EOCM2A_K2_FO,EOCM2A_K1_FO
 SG_ AdvDrAstMpSegOffset : 52|13@0+ (1,0) [0|8191] "m"  EOCM2B_IMX6_FO,EOCM2B_K2_FO,EOCM2B_K1_FO,EOCM2A_IMX6_FO,EOCM2A_K2_FO,EOCM2A_K1_FO

BO_ 608 PPS_ElevHdSpd_FO: 8 EOCM2A_K1_FO
 SG_ PPSVel : 31|8@0+ (1,0) [0|255] "km / h"  EOCM2B_IMX6_FO,EOCM2B_K2_FO,EOCM2B_K1_FO,AMM_FO
 SG_ PPSVelV : 3|1@0+ (1,0) [0|1] ""  EOCM2B_IMX6_FO,EOCM2B_K2_FO,EOCM2B_K1_FO,AMM_FO
 SG_ PPSElvHedngSpdBrstID : 5|2@0+ (1,0) [0|3] ""  EOCM2B_IMX6_FO,EOCM2B_K2_FO,EOCM2B_K1_FO,AMM_FO
 SG_ PPSElvHdengSpdChksm : 50|11@0+ (1,0) [0|2047] ""  EOCM2B_IMX6_FO,EOCM2B_K2_FO,EOCM2B_K1_FO,AMM_FO
 SG_ PPSHedngV : 6|1@0+ (1,0) [0|1] ""  EOCM2B_IMX6_FO,EOCM2B_K2_FO,EOCM2B_K1_FO,AMM_FO
 SG_ PPSHedng : 2|19@0+ (0.001,0) [0|524.287] "deg"  EOCM2B_IMX6_FO,EOCM2B_K2_FO,EOCM2B_K1_FO,AMM_FO
 SG_ PPSElvtnV : 7|1@0+ (1,0) [0|1] ""  EOCM2B_IMX6_FO,EOCM2B_K2_FO,EOCM2B_K1_FO,AMM_FO
 SG_ PPSElvtn : 39|21@0+ (1,-100000) [-100000|1997151] "cm"  EOCM2B_IMX6_FO,EOCM2B_K2_FO,EOCM2B_K1_FO,AMM_FO

BO_ 1168 WiFi_Station_AMM_FO: 5 AMM_FO
 SG_ WSMR_WiFiStnMpMACAddr : 15|32@0+ (1,0) [0|4294967295] ""  EOCM2B_K1_FO,EOCM2A_K1_FO
 SG_ WSMR_WiFiAssnReq : 1|2@0+ (1,0) [0|3] ""  EOCM2B_K1_FO,EOCM2A_K1_FO

BO_ 1161 WiFi_AP_Data_AMM_FO: 2 EOCM2A_K1_FO
 SG_ WAPDM_SecurityType : 15|4@0+ (1,0) [0|15] ""  EOCM2B_K1_FO,AMM_FO
 SG_ WAPDM_WiFiEnStat : 0|1@0+ (1,0) [0|1] ""  EOCM2B_K1_FO,AMM_FO
 SG_ WAPDM_EncrptnType : 11|4@0+ (1,0) [0|15] ""  EOCM2B_K1_FO,AMM_FO

BO_ 1157 SSID_AMM_3_FO: 8 EOCM2A_K1_FO
 SG_ WiFiSSIDDgts17to24_Mp : 7|64@0+ (1,0) [0|0] ""  EOCM2B_K1_FO,AMM_FO

BO_ 326 DMS_Eye_AOI_Info_FO: 6 DMS_FO
 SG_ DrvrMontSysInit : 1|1@0+ (1,0) [0|1] ""  EOCM2B_IMX6_FO,EOCM2B_K2_FO,EOCM2B_K1_FO,EOCM2A_IMX6_FO,EOCM2A_K2_FO,EOCM2A_K1_FO
 SG_ DrvrMontSysAvlbl : 3|1@0+ (1,0) [0|1] ""  EOCM2B_IMX6_FO,EOCM2B_K2_FO,EOCM2B_K1_FO,EOCM2A_IMX6_FO,EOCM2A_K2_FO,EOCM2A_K1_FO
 SG_ DrvrMontMdlDatFlshProgrs : 2|1@0+ (1,0) [0|1] ""  EOCM2B_IMX6_FO,EOCM2B_K2_FO,EOCM2B_K1_FO,EOCM2A_IMX6_FO,EOCM2A_K2_FO,EOCM2A_K1_FO
 SG_ DrvrMonEngRecvrFltCodARC : 36|2@0+ (1,0) [0|3] ""  EOCM2B_IMX6_FO,EOCM2B_K2_FO,EOCM2B_K1_FO,EOCM2A_IMX6_FO,EOCM2A_K2_FO,EOCM2A_K1_FO
 SG_ DrvrAttnStatChksm : 34|11@0+ (1,0) [0|2047] ""  EOCM2B_IMX6_FO,EOCM2B_K2_FO,EOCM2B_K1_FO,EOCM2A_IMX6_FO,EOCM2A_K2_FO,EOCM2A_K1_FO
 SG_ DrvrAttnStat : 39|3@0+ (1,0) [0|7] ""  EOCM2B_IMX6_FO,EOCM2B_K2_FO,EOCM2B_K1_FO,EOCM2A_IMX6_FO,EOCM2A_K2_FO,EOCM2A_K1_FO
 SG_ DrvrAttnStatPrd : 22|15@0+ (0.025,0) [0|819.175] ""  EOCM2B_IMX6_FO,EOCM2B_K2_FO,EOCM2B_K1_FO,EOCM2A_IMX6_FO,EOCM2A_K2_FO,EOCM2A_K1_FO
 SG_ DrvrMonEngRecvrFltCodV : 23|1@0+ (1,0) [0|1] ""  EOCM2B_IMX6_FO,EOCM2B_K2_FO,EOCM2B_K1_FO,EOCM2A_IMX6_FO,EOCM2A_K2_FO,EOCM2A_K1_FO
 SG_ DrvrMonEngUnrecvrFltCod : 10|3@0+ (1,0) [0|7] ""  EOCM2B_IMX6_FO,EOCM2B_K2_FO,EOCM2B_K1_FO,EOCM2A_IMX6_FO,EOCM2A_K2_FO,EOCM2A_K1_FO
 SG_ DrvrMonEngUnrecvrFltCodV : 11|1@0+ (1,0) [0|1] ""  EOCM2B_IMX6_FO,EOCM2B_K2_FO,EOCM2B_K1_FO,EOCM2A_IMX6_FO,EOCM2A_K2_FO,EOCM2A_K1_FO
 SG_ DrvrAttnStatCnfdc : 13|2@0+ (1,0) [0|3] ""  EOCM2B_IMX6_FO,EOCM2B_K2_FO,EOCM2B_K1_FO,EOCM2A_IMX6_FO,EOCM2A_K2_FO,EOCM2A_K1_FO
 SG_ DrvrMonEngRecvrFltCod : 15|2@0+ (1,0) [0|3] ""  EOCM2B_IMX6_FO,EOCM2B_K2_FO,EOCM2B_K1_FO,EOCM2A_IMX6_FO,EOCM2A_K2_FO,EOCM2A_K1_FO
 SG_ DrvrAttnStatV : 0|1@0+ (1,0) [0|1] ""  EOCM2B_IMX6_FO,EOCM2B_K2_FO,EOCM2B_K1_FO,EOCM2A_IMX6_FO,EOCM2A_K2_FO,EOCM2A_K1_FO

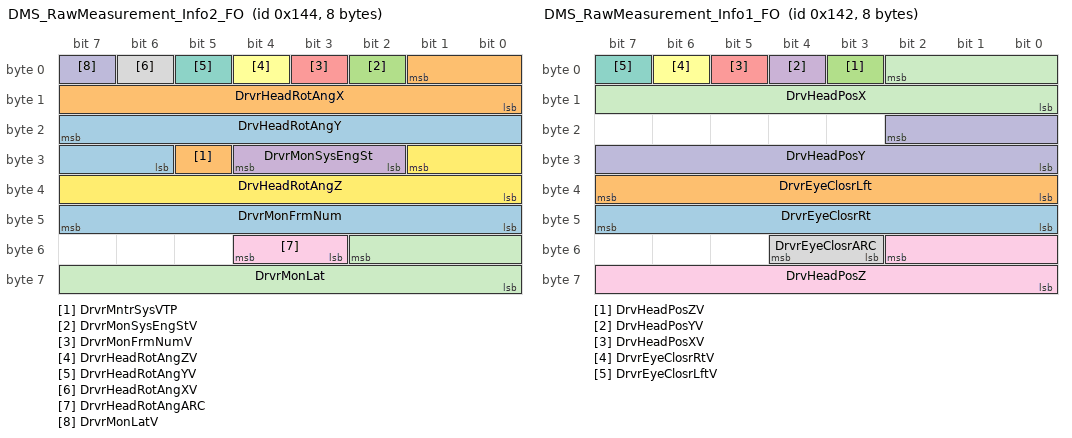
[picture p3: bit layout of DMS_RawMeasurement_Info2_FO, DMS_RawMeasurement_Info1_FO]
BO_ 324 DMS_RawMeasurement_Info2_FO: 8 DMS_FO
 SG_ DrvrMonFrmNum : 47|8@0+ (1,0) [0|255] ""  EOCM2B_IMX6_FO,EOCM2B_K2_FO,EOCM2B_K1_FO,EOCM2A_IMX6_FO,EOCM2A_K2_FO,EOCM2A_K1_FO
 SG_ DrvrMntrSysVTP : 29|1@0+ (1,0) [0|1] ""  EOCM2B_IMX6_FO,EOCM2B_K2_FO,EOCM2B_K1_FO,EOCM2A_IMX6_FO,EOCM2A_K2_FO,EOCM2A_K1_FO
 SG_ DrvrMonSysEngStV : 2|1@0+ (1,0) [0|1] ""  EOCM2B_IMX6_FO,EOCM2B_K2_FO,EOCM2B_K1_FO,EOCM2A_IMX6_FO,EOCM2A_K2_FO,EOCM2A_K1_FO
 SG_ DrvrMonSysEngSt : 28|3@0+ (1,0) [0|7] ""  EOCM2B_IMX6_FO,EOCM2B_K2_FO,EOCM2B_K1_FO,EOCM2A_IMX6_FO,EOCM2A_K2_FO,EOCM2A_K1_FO
 SG_ DrvrMonFrmNumV : 3|1@0+ (1,0) [0|1] ""  EOCM2B_IMX6_FO,EOCM2B_K2_FO,EOCM2B_K1_FO,EOCM2A_IMX6_FO,EOCM2A_K2_FO,EOCM2A_K1_FO
 SG_ DrvrHeadRotAngZV : 4|1@0+ (1,0) [0|1] ""  EOCM2B_IMX6_FO,EOCM2B_K2_FO,EOCM2B_K1_FO,EOCM2A_IMX6_FO,EOCM2A_K2_FO,EOCM2A_K1_FO
 SG_ DrvrHeadRotAngYV : 5|1@0+ (1,0) [0|1] ""  EOCM2B_IMX6_FO,EOCM2B_K2_FO,EOCM2B_K1_FO,EOCM2A_IMX6_FO,EOCM2A_K2_FO,EOCM2A_K1_FO
 SG_ DrvrHeadRotAngXV : 6|1@0+ (1,0) [0|1] ""  EOCM2B_IMX6_FO,EOCM2B_K2_FO,EOCM2B_K1_FO,EOCM2A_IMX6_FO,EOCM2A_K2_FO,EOCM2A_K1_FO
 SG_ DrvrHeadRotAngARC : 52|2@0+ (1,0) [0|3] ""  EOCM2B_IMX6_FO,EOCM2B_K2_FO,EOCM2B_K1_FO,EOCM2A_IMX6_FO,EOCM2A_K2_FO,EOCM2A_K1_FO
 SG_ DrvrMonLatV : 7|1@0+ (1,0) [0|1] ""  EOCM2B_IMX6_FO,EOCM2B_K2_FO,EOCM2B_K1_FO,EOCM2A_IMX6_FO,EOCM2A_K2_FO,EOCM2A_K1_FO
 SG_ DrvrMonLat : 50|11@0+ (0.001,0) [0|2.047] ""  EOCM2B_IMX6_FO,EOCM2B_K2_FO,EOCM2B_K1_FO,EOCM2A_IMX6_FO,EOCM2A_K2_FO,EOCM2A_K1_FO
 SG_ DrvHeadRotAngZ : 25|10@0- (0.00625,0) [-3.2|3.19375] "rad"  EOCM2A_IMX6_FO,EOCM2A_K2_FO,EOCM2A_K1_FO,EOCM2B_IMX6_FO,EOCM2B_K2_FO,EOCM2B_K1_FO
 SG_ DrvHeadRotAngY : 23|10@0- (0.00625,0) [-3.2|3.19375] "rad"  EOCM2A_IMX6_FO,EOCM2A_K2_FO,EOCM2A_K1_FO,EOCM2B_IMX6_FO,EOCM2B_K2_FO,EOCM2B_K1_FO
 SG_ DrvrHeadRotAngX : 1|10@0- (0.00625,0) [-3.2|3.19375] "rad"  EOCM2A_IMX6_FO,EOCM2A_K2_FO,EOCM2A_K1_FO,EOCM2B_IMX6_FO,EOCM2B_K2_FO,EOCM2B_K1_FO

BO_ 322 DMS_RawMeasurement_Info1_FO: 8 DMS_FO
 SG_ DrvrEyeClosrRt : 47|8@0+ (0.005,0) [0|1.275] ""  EOCM2B_IMX6_FO,EOCM2B_K2_FO,EOCM2B_K1_FO,EOCM2A_IMX6_FO,EOCM2A_K2_FO,EOCM2A_K1_FO
 SG_ DrvrEyeClosrLft : 39|8@0+ (0.005,0) [0|1.275] ""  EOCM2B_IMX6_FO,EOCM2B_K2_FO,EOCM2B_K1_FO,EOCM2A_IMX6_FO,EOCM2A_K2_FO,EOCM2A_K1_FO
 SG_ DrvHeadPosZV : 3|1@0+ (1,0) [0|1] ""  EOCM2B_IMX6_FO,EOCM2B_K2_FO,EOCM2B_K1_FO,EOCM2A_IMX6_FO,EOCM2A_K2_FO,EOCM2A_K1_FO
 SG_ DrvHeadPosYV : 4|1@0+ (1,0) [0|1] ""  EOCM2B_IMX6_FO,EOCM2B_K2_FO,EOCM2B_K1_FO,EOCM2A_IMX6_FO,EOCM2A_K2_FO,EOCM2A_K1_FO
 SG_ DrvHeadPosXV : 5|1@0+ (1,0) [0|1] ""  EOCM2B_IMX6_FO,EOCM2B_K2_FO,EOCM2B_K1_FO,EOCM2A_IMX6_FO,EOCM2A_K2_FO,EOCM2A_K1_FO
 SG_ DrvrEyeClosrRtV : 6|1@0+ (1,0) [0|1] ""  EOCM2B_IMX6_FO,EOCM2B_K2_FO,EOCM2B_K1_FO,EOCM2A_IMX6_FO,EOCM2A_K2_FO,EOCM2A_K1_FO
 SG_ DrvrEyeClosrLftV : 7|1@0+ (1,0) [0|1] ""  EOCM2B_IMX6_FO,EOCM2B_K2_FO,EOCM2B_K1_FO,EOCM2A_IMX6_FO,EOCM2A_K2_FO,EOCM2A_K1_FO
 SG_ DrvrEyeClosrARC : 52|2@0+ (1,0) [0|3] ""  EOCM2B_IMX6_FO,EOCM2B_K2_FO,EOCM2B_K1_FO,EOCM2A_IMX6_FO,EOCM2A_K2_FO,EOCM2A_K1_FO
 SG_ DrvHeadPosZ : 50|11@0- (0.005,0) [-5.12|5.115] "m"  EOCM2A_IMX6_FO,EOCM2A_K2_FO,EOCM2A_K1_FO,EOCM2B_IMX6_FO,EOCM2B_K2_FO,EOCM2B_K1_FO
 SG_ DrvHeadPosY : 18|11@0- (0.005,0) [-5.12|5.115] "m"  EOCM2A_IMX6_FO,EOCM2A_K2_FO,EOCM2A_K1_FO,EOCM2B_IMX6_FO,EOCM2B_K2_FO,EOCM2B_K1_FO
 SG_ DrvHeadPosX : 2|11@0- (0.005,0) [-5.12|5.115] "m"  EOCM2A_IMX6_FO,EOCM2A_K2_FO,EOCM2A_K1_FO,EOCM2B_IMX6_FO,EOCM2B_K2_FO,EOCM2B_K1_FO

BO_ 320 Inertial2_Rates_FO: 8 _DOFIMU2_FO
 SG_ MstrTgrSyncInrtl2Rte : 55|5@0+ (1,0) [0|31] ""  EOCM2A_IMX6_FO,EOCM2A_K2_FO,EOCM2A_K1_FO,EOCM2B_IMX6_FO,EOCM2B_K2_FO,EOCM2B_K1_FO
 SG_ Inertial2YawRteV : 5|1@0+ (1,0) [0|1] ""  EOCM2A_IMX6_FO,EOCM2A_K2_FO,EOCM2A_K1_FO,EOCM2B_IMX6_FO,EOCM2B_K2_FO,EOCM2B_K1_FO
 SG_ Inertial2YawRte : 36|13@0- (0.024,0) [-98.304|98.28] "deg/s"  EOCM2A_IMX6_FO,EOCM2A_K2_FO,EOCM2A_K1_FO,EOCM2B_IMX6_FO,EOCM2B_K2_FO,EOCM2B_K1_FO
 SG_ Inertial2RollRteV : 6|1@0+ (1,0) [0|1] ""  EOCM2A_IMX6_FO,EOCM2A_K2_FO,EOCM2A_K1_FO,EOCM2B_IMX6_FO,EOCM2B_K2_FO,EOCM2B_K1_FO
 SG_ Inertial2RollRte : 20|13@0- (0.024,0) [-98.304|98.28] "deg/s"  EOCM2A_IMX6_FO,EOCM2A_K2_FO,EOCM2A_K1_FO,EOCM2B_IMX6_FO,EOCM2B_K2_FO,EOCM2B_K1_FO
 SG_ Inertial2RteChksum : 50|11@0+ (1,0) [0|2047] ""  EOCM2A_IMX6_FO,EOCM2A_K2_FO,EOCM2A_K1_FO,EOCM2B_IMX6_FO,EOCM2B_K2_FO,EOCM2B_K1_FO
 SG_ Inertial2PitchRteV : 7|1@0+ (1,0) [0|1] ""  EOCM2A_IMX6_FO,EOCM2A_K2_FO,EOCM2A_K1_FO,EOCM2B_IMX6_FO,EOCM2B_K2_FO,EOCM2B_K1_FO
 SG_ Inertial2PitchRte : 4|13@0- (0.024,0) [-98.304|98.28] "deg/s"  EOCM2A_IMX6_FO,EOCM2A_K2_FO,EOCM2A_K1_FO,EOCM2B_IMX6_FO,EOCM2B_K2_FO,EOCM2B_K1_FO

BO_ 308 Inertial1_Rates_FO: 8 _DOFIMU1_FO
 SG_ MstrTrgrSyncInrtl1Rte : 55|5@0+ (1,0) [0|31] ""  EOCM2A_IMX6_FO,EOCM2A_K2_FO,EOCM2A_K1_FO,EOCM2B_IMX6_FO,EOCM2B_K2_FO,EOCM2B_K1_FO
 SG_ Inertial1YawRteV : 5|1@0+ (1,0) [0|1] ""  EOCM2A_IMX6_FO,EOCM2A_K2_FO,EOCM2A_K1_FO,EOCM2B_IMX6_FO,EOCM2B_K2_FO,EOCM2B_K1_FO
 SG_ Inertial1YawRte : 36|13@0- (0.024,0) [-98.304|98.28] "deg/s"  EOCM2A_IMX6_FO,EOCM2A_K2_FO,EOCM2A_K1_FO,EOCM2B_IMX6_FO,EOCM2B_K2_FO,EOCM2B_K1_FO
 SG_ Inertial1RollRteV : 6|1@0+ (1,0) [0|1] ""  EOCM2A_IMX6_FO,EOCM2A_K2_FO,EOCM2A_K1_FO,EOCM2B_IMX6_FO,EOCM2B_K2_FO,EOCM2B_K1_FO
 SG_ Inertial1RollRte : 20|13@0- (0.024,0) [-98.304|98.28] "deg/s"  EOCM2A_IMX6_FO,EOCM2A_K2_FO,EOCM2A_K1_FO,EOCM2B_IMX6_FO,EOCM2B_K2_FO,EOCM2B_K1_FO
 SG_ Inertial1RteChksum : 50|11@0+ (1,0) [0|2047] ""  EOCM2A_IMX6_FO,EOCM2A_K2_FO,EOCM2A_K1_FO,EOCM2B_IMX6_FO,EOCM2B_K2_FO,EOCM2B_K1_FO
 SG_ Inertial1PitchRteV : 7|1@0+ (1,0) [0|1] ""  EOCM2A_IMX6_FO,EOCM2A_K2_FO,EOCM2A_K1_FO,EOCM2B_IMX6_FO,EOCM2B_K2_FO,EOCM2B_K1_FO
 SG_ Inertial1PitchRte : 4|13@0- (0.024,0) [-98.304|98.28] "deg/s"  EOCM2A_IMX6_FO,EOCM2A_K2_FO,EOCM2A_K1_FO,EOCM2B_IMX6_FO,EOCM2B_K2_FO,EOCM2B_K1_FO

BO_ 312 Inertial2_Accel2_FO: 8 _DOFIMU2_FO
 SG_ MstrTrigSyncInrtl22 : 55|5@0+ (1,0) [0|31] ""  EOCM2A_IMX6_FO,EOCM2A_K2_FO,EOCM2A_K1_FO,EOCM2B_IMX6_FO,EOCM2B_K2_FO,EOCM2B_K1_FO
 SG_ InrtlSns2AccFrm2Chksm : 50|11@0+ (1,0) [0|2047] ""  EOCM2A_IMX6_FO,EOCM2A_K2_FO,EOCM2A_K1_FO,EOCM2B_IMX6_FO,EOCM2B_K2_FO,EOCM2B_K1_FO
 SG_ InrtlSnsr2YawAccV : 5|1@0+ (1,0) [0|1] ""  EOCM2A_IMX6_FO,EOCM2A_K2_FO,EOCM2A_K1_FO,EOCM2B_IMX6_FO,EOCM2B_K2_FO,EOCM2B_K1_FO
 SG_ InrtlSnsr2YawAcc : 36|13@0- (0.024,0) [-98.304|98.28] "deg/s^2"  EOCM2A_IMX6_FO,EOCM2A_K2_FO,EOCM2A_K1_FO,EOCM2B_IMX6_FO,EOCM2B_K2_FO,EOCM2B_K1_FO
 SG_ InrtlSnsr2RollAccV : 6|1@0+ (1,0) [0|1] ""  EOCM2A_IMX6_FO,EOCM2A_K2_FO,EOCM2A_K1_FO,EOCM2B_IMX6_FO,EOCM2B_K2_FO,EOCM2B_K1_FO
 SG_ InrtlSnsr2RollAcc : 20|13@0- (0.024,0) [-98.304|98.28] "deg/s^2"  EOCM2A_IMX6_FO,EOCM2A_K2_FO,EOCM2A_K1_FO,EOCM2B_IMX6_FO,EOCM2B_K2_FO,EOCM2B_K1_FO
 SG_ InrtlSnsr2PtchAccV : 7|1@0+ (1,0) [0|1] ""  EOCM2A_IMX6_FO,EOCM2A_K2_FO,EOCM2A_K1_FO,EOCM2B_IMX6_FO,EOCM2B_K2_FO,EOCM2B_K1_FO
 SG_ InrtlSnsr2PtchAcc : 4|13@0- (0.024,0) [-98.304|98.28] "deg/s^2"  EOCM2A_IMX6_FO,EOCM2A_K2_FO,EOCM2A_K1_FO,EOCM2B_IMX6_FO,EOCM2B_K2_FO,EOCM2B_K1_FO

BO_ 306 Inertial1_Accel2_FO: 8 _DOFIMU1_FO
 SG_ MstrTrigSyncInrtl12 : 55|5@0+ (1,0) [0|31] ""  EOCM2A_IMX6_FO,EOCM2A_K2_FO,EOCM2A_K1_FO,EOCM2B_IMX6_FO,EOCM2B_K2_FO,EOCM2B_K1_FO
 SG_ InrtlSnsr1AccelFrm2Chksm : 50|11@0+ (1,0) [0|2047] ""  EOCM2A_IMX6_FO,EOCM2A_K2_FO,EOCM2A_K1_FO,EOCM2B_IMX6_FO,EOCM2B_K2_FO,EOCM2B_K1_FO
 SG_ InrtlSnsr1YawAccV : 5|1@0+ (1,0) [0|1] ""  EOCM2A_IMX6_FO,EOCM2A_K2_FO,EOCM2A_K1_FO,EOCM2B_IMX6_FO,EOCM2B_K2_FO,EOCM2B_K1_FO
 SG_ InrtlSnsr1YawAcc : 36|13@0- (0.024,0) [-98.304|98.28] "deg/s^2"  EOCM2A_IMX6_FO,EOCM2A_K2_FO,EOCM2A_K1_FO,EOCM2B_IMX6_FO,EOCM2B_K2_FO,EOCM2B_K1_FO
 SG_ InrtlSnsr1RollAccV : 6|1@0+ (1,0) [0|1] ""  EOCM2A_IMX6_FO,EOCM2A_K2_FO,EOCM2A_K1_FO,EOCM2B_IMX6_FO,EOCM2B_K2_FO,EOCM2B_K1_FO
 SG_ InrtlSnsr1RollAcc : 20|13@0- (0.024,0) [-98.304|98.28] "deg/s^2"  EOCM2A_IMX6_FO,EOCM2A_K2_FO,EOCM2A_K1_FO,EOCM2B_IMX6_FO,EOCM2B_K2_FO,EOCM2B_K1_FO
 SG_ InrtlSnsr1PtchAccV : 7|1@0+ (1,0) [0|1] ""  EOCM2A_IMX6_FO,EOCM2A_K2_FO,EOCM2A_K1_FO,EOCM2B_IMX6_FO,EOCM2B_K2_FO,EOCM2B_K1_FO
 SG_ InrtlSnsr1PtchAcc : 4|13@0- (0.024,0) [-98.304|98.28] "deg/s^2"  EOCM2A_IMX6_FO,EOCM2A_K2_FO,EOCM2A_K1_FO,EOCM2B_IMX6_FO,EOCM2B_K2_FO,EOCM2B_K1_FO

BO_ 310 Inertial2_Accel1_FO: 8 _DOFIMU2_FO
 SG_ MstrTrigSyncInrtl21 : 7|5@0+ (1,0) [0|31] ""  EOCM2A_IMX6_FO,EOCM2A_K2_FO,EOCM2A_K1_FO,EOCM2B_IMX6_FO,EOCM2B_K2_FO,EOCM2B_K1_FO
 SG_ Inertial2VertAccV : 34|1@0+ (1,0) [0|1] ""  EOCM2A_IMX6_FO,EOCM2A_K2_FO,EOCM2A_K1_FO,EOCM2B_IMX6_FO,EOCM2B_K2_FO,EOCM2B_K1_FO
 SG_ Inertial2VertAcc : 33|10@0- (0.0625,0) [-32|31.9375] "m/s^2"  EOCM2A_IMX6_FO,EOCM2A_K2_FO,EOCM2A_K1_FO,EOCM2B_IMX6_FO,EOCM2B_K2_FO,EOCM2B_K1_FO
 SG_ Inertial2LonAccV : 2|1@0+ (1,0) [0|1] ""  EOCM2A_IMX6_FO,EOCM2A_K2_FO,EOCM2A_K1_FO,EOCM2B_IMX6_FO,EOCM2B_K2_FO,EOCM2B_K1_FO
 SG_ Inertial2LonAcc : 1|10@0- (0.0625,0) [-32|31.9375] "m/s^2"  EOCM2A_IMX6_FO,EOCM2A_K2_FO,EOCM2A_K1_FO,EOCM2B_IMX6_FO,EOCM2B_K2_FO,EOCM2B_K1_FO
 SG_ Inertial2LatAccV : 18|1@0+ (1,0) [0|1] ""  EOCM2A_IMX6_FO,EOCM2A_K2_FO,EOCM2A_K1_FO,EOCM2B_IMX6_FO,EOCM2B_K2_FO,EOCM2B_K1_FO
 SG_ Inertial2LatAcc : 17|10@0- (0.0625,0) [-32|31.9375] "m/s^2"  EOCM2A_IMX6_FO,EOCM2A_K2_FO,EOCM2A_K1_FO,EOCM2B_IMX6_FO,EOCM2B_K2_FO,EOCM2B_K1_FO
 SG_ IntlSnsr2AcelFm1Chksm : 50|11@0+ (1,0) [0|2047] ""  EOCM2A_IMX6_FO,EOCM2A_K2_FO,EOCM2A_K1_FO,EOCM2B_IMX6_FO,EOCM2B_K2_FO,EOCM2B_K1_FO

BO_ 304 Inertial1_Accel1_FO: 8 _DOFIMU1_FO
 SG_ MstrTrigSyncInrtl11 : 7|5@0+ (1,0) [0|31] ""  EOCM2A_IMX6_FO,EOCM2A_K2_FO,EOCM2A_K1_FO,EOCM2B_IMX6_FO,EOCM2B_K2_FO,EOCM2B_K1_FO
 SG_ InrtlSnsr1VertAccV : 34|1@0+ (1,0) [0|1] ""  EOCM2A_IMX6_FO,EOCM2A_K2_FO,EOCM2A_K1_FO,EOCM2B_IMX6_FO,EOCM2B_K2_FO,EOCM2B_K1_FO
 SG_ InrtlSnsr1VertAcc : 33|10@0- (0.0625,0) [-32|31.9375] "m/s^2"  EOCM2A_IMX6_FO,EOCM2A_K2_FO,EOCM2A_K1_FO,EOCM2B_IMX6_FO,EOCM2B_K2_FO,EOCM2B_K1_FO
 SG_ InrtlSnsr1LonAccV : 2|1@0+ (1,0) [0|1] ""  EOCM2A_IMX6_FO,EOCM2A_K2_FO,EOCM2A_K1_FO,EOCM2B_IMX6_FO,EOCM2B_K2_FO,EOCM2B_K1_FO
 SG_ InrtlSnsr1LonAcc : 1|10@0- (0.0625,0) [-32|31.9375] "m/s^2"  EOCM2A_IMX6_FO,EOCM2A_K2_FO,EOCM2A_K1_FO,EOCM2B_IMX6_FO,EOCM2B_K2_FO,EOCM2B_K1_FO
 SG_ InrtlSnsr1LatAccV : 18|1@0+ (1,0) [0|1] ""  EOCM2A_IMX6_FO,EOCM2A_K2_FO,EOCM2A_K1_FO,EOCM2B_IMX6_FO,EOCM2B_K2_FO,EOCM2B_K1_FO
 SG_ InrtlSnsr1LatAcc : 17|10@0- (0.0625,0) [-32|31.9375] "m/s^2"  EOCM2A_IMX6_FO,EOCM2A_K2_FO,EOCM2A_K1_FO,EOCM2B_IMX6_FO,EOCM2B_K2_FO,EOCM2B_K1_FO
 SG_ IntlSnsr1AcelFm1Chksm : 50|11@0+ (1,0) [0|2047] ""  EOCM2A_IMX6_FO,EOCM2A_K2_FO,EOCM2A_K1_FO,EOCM2B_IMX6_FO,EOCM2B_K2_FO,EOCM2B_K1_FO

BO_ 356 Map_Pos_Correction_FO: 4 EOCM2A_K1_FO
 SG_ LongErrPstn : 7|8@0- (0.5,0) [-64|63.5] "m"  AMM_FO,EOCM2B_IMX6_FO,EOCM2B_K2_FO,EOCM2B_K1_FO
 SG_ LatErrPstn : 15|8@0- (0.5,0) [-64|63.5] "m"  AMM_FO,EOCM2B_IMX6_FO,EOCM2B_K2_FO,EOCM2B_K1_FO
 SG_ PstnErrChcksm : 18|11@0+ (1,0) [0|2047] ""  AMM_FO,EOCM2B_IMX6_FO,EOCM2B_K2_FO,EOCM2B_K1_FO
 SG_ PstnErrARC : 20|2@0+ (1,0) [0|3] ""  AMM_FO,EOCM2B_IMX6_FO,EOCM2B_K2_FO,EOCM2B_K1_FO

BO_ 354 Map_Retrans_Request_FO: 1 EOCM2A_K1_FO
 SG_ HrznPrvdRstRq : 2|1@0+ (1,0) [0|1] ""  AMM_FO,EOCM2B_IMX6_FO,EOCM2B_K2_FO,EOCM2B_K1_FO
 SG_ ADASISRwDtMplxdCycCnt : 7|2@0+ (1,0) [0|3] ""  AMM_FO,EOCM2B_IMX6_FO,EOCM2B_K2_FO,EOCM2B_K1_FO
 SG_ ADASISMsgTypRetrans : 5|3@0+ (1,0) [0|7] ""  AMM_FO,EOCM2B_IMX6_FO,EOCM2B_K2_FO,EOCM2B_K1_FO

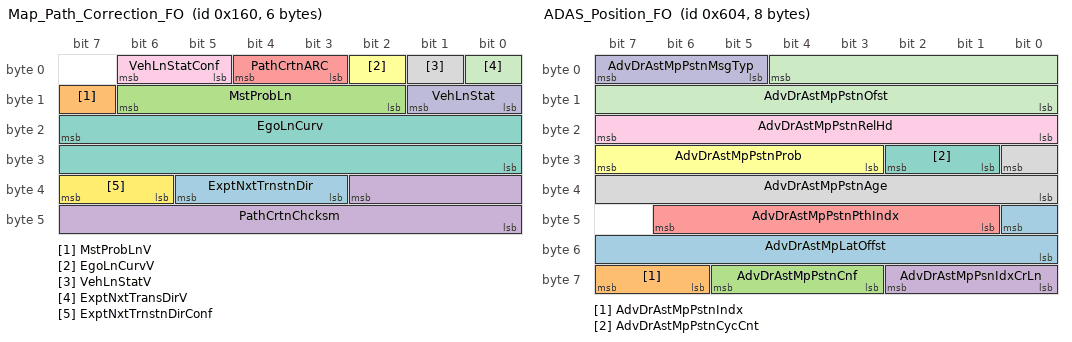
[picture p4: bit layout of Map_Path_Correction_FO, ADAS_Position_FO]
BO_ 352 Map_Path_Correction_FO: 6 EOCM2A_K1_FO
 SG_ ExptNxtTrnstnDir : 37|3@0+ (1,0) [0|7] ""  AMM_FO,EOCM2B_IMX6_FO,EOCM2B_K2_FO,EOCM2B_K1_FO
 SG_ MstProbLnV : 15|1@0+ (1,0) [0|1] ""  AMM_FO
 SG_ MstProbLn : 14|5@0+ (1,0) [0|31] ""  AMM_FO
 SG_ PathCrtnChcksm : 34|11@0+ (1,0) [0|2047] ""  AMM_FO,EOCM2B_IMX6_FO,EOCM2B_K2_FO,EOCM2B_K1_FO
 SG_ PathCrtnARC : 4|2@0+ (1,0) [0|3] ""  AMM_FO,EOCM2B_IMX6_FO,EOCM2B_K2_FO,EOCM2B_K1_FO
 SG_ EgoLnCurvV : 2|1@0+ (1,0) [0|1] ""  AMM_FO,EOCM2B_IMX6_FO,EOCM2B_K2_FO,EOCM2B_K1_FO
 SG_ EgoLnCurv : 23|16@0- (9.53E-007,0) [-0.031227904|0.031226951] "1/m^2"  AMM_FO,EOCM2B_IMX6_FO,EOCM2B_K2_FO,EOCM2B_K1_FO
 SG_ VehLnStatV : 1|1@0+ (1,0) [0|1] ""  AMM_FO,EOCM2B_IMX6_FO,EOCM2B_K2_FO,EOCM2B_K1_FO
 SG_ VehLnStatConf : 6|2@0+ (1,0) [0|3] ""  AMM_FO,EOCM2B_IMX6_FO,EOCM2B_K2_FO,EOCM2B_K1_FO
 SG_ VehLnStat : 9|2@0+ (1,0) [0|3] ""  AMM_FO,EOCM2B_IMX6_FO,EOCM2B_K2_FO,EOCM2B_K1_FO
 SG_ ExptNxtTransDirV : 0|1@0+ (1,0) [0|1] ""  AMM_FO,EOCM2B_IMX6_FO,EOCM2B_K2_FO,EOCM2B_K1_FO
 SG_ ExptNxtTrnstnDirConf : 39|2@0+ (1,0) [0|3] ""  AMM_FO,EOCM2B_IMX6_FO,EOCM2B_K2_FO,EOCM2B_K1_FO

BO_ 264 Inertial_Trigger_FO: 1 EOCM2A_K1_FO
 SG_ InrtlSnsrMstrTrgrSync : 7|5@0+ (1,0) [0|31] ""  EOCM2B_IMX6_FO,EOCM2B_K2_FO,EOCM2B_K1_FO,_DOFIMU2_FO,_DOFIMU1_FO

BO_ 1156 SSID_AMM_2_FO: 8 EOCM2A_K1_FO
 SG_ WiFiSSIDDgts9to16_Mp : 7|64@0+ (1,0) [0|0] ""  EOCM2B_K1_FO,AMM_FO

BO_ 1155 SSID_AMM_1_FO: 8 EOCM2A_K1_FO
 SG_ WiFiSSIDDgts1to8_Mp : 7|64@0+ (1,0) [0|0] ""  EOCM2B_K1_FO,AMM_FO

BO_ 1927 DTC_Triggered_787_FO: 7 DMS_FO
 SG_ DTCI_CodeSupported_787 : 40|1@0+ (1,0) [0|1] ""  TestTool_FO
 SG_ DTCI_CurrentStatus_787 : 41|1@0+ (1,0) [0|1] ""  TestTool_FO
 SG_ DTCI_DTCFailType_787 : 39|8@0+ (1,0) [0|255] ""  TestTool_FO
 SG_ DTCI_DTCFaultType_787 : 55|8@0+ (1,0) [0|255] ""  TestTool_FO
 SG_ DTCI_DTCNumber_787 : 23|16@0+ (1,0) [0|65535] ""  TestTool_FO
 SG_ DTCI_DTCSource_787 : 15|8@0+ (1,0) [0|255] ""  TestTool_FO
 SG_ DTCI_DTCTriggered_787 : 0|1@0+ (1,0) [0|1] ""  TestTool_FO
 SG_ DTCI_HistStat_787 : 44|1@0+ (1,0) [0|1] ""  TestTool_FO
 SG_ DTCI_TstFldCdClrdStat_787 : 43|1@0+ (1,0) [0|1] ""  TestTool_FO
 SG_ DTCI_TstFldPwrUpSt_787 : 46|1@0+ (1,0) [0|1] ""  TestTool_FO
 SG_ DTCI_TstNPsdCdClrdSt_787 : 42|1@0+ (1,0) [0|1] ""  TestTool_FO
 SG_ DTCI_TstNPsdPwrUpSt_787 : 45|1@0+ (1,0) [0|1] ""  TestTool_FO
 SG_ DTCIUnused1_787 : 7|1@0+ (1,0) [0|1] ""  TestTool_FO
 SG_ DTCIUnused2_787 : 6|1@0+ (1,0) [0|1] ""  TestTool_FO
 SG_ DTCIUnused3_787 : 5|1@0+ (1,0) [0|1] ""  TestTool_FO
 SG_ DTCIUnused4_787 : 4|1@0+ (1,0) [0|1] ""  TestTool_FO
 SG_ DTCIUnused5_787 : 3|1@0+ (1,0) [0|1] ""  TestTool_FO
 SG_ DTCIUnused6_787 : 2|1@0+ (1,0) [0|1] ""  TestTool_FO
 SG_ DTCIUnused7_787 : 1|1@0+ (1,0) [0|1] ""  TestTool_FO
 SG_ DTCI_WrnIndRqdSt_787 : 47|1@0+ (1,0) [0|1] ""  TestTool_FO

BO_ 1926 DTC_Triggered_786_FO: 7 AMM_FO
 SG_ DTCI_CodeSupported_786 : 40|1@0+ (1,0) [0|1] ""  TestTool_FO
 SG_ DTCI_CurrentStatus_786 : 41|1@0+ (1,0) [0|1] ""  TestTool_FO
 SG_ DTCI_DTCFailType_786 : 39|8@0+ (1,0) [0|255] ""  TestTool_FO
 SG_ DTCI_DTCFaultType_786 : 55|8@0+ (1,0) [0|255] ""  TestTool_FO
 SG_ DTCI_DTCNumber_786 : 23|16@0+ (1,0) [0|65535] ""  TestTool_FO
 SG_ DTCI_DTCSource_786 : 15|8@0+ (1,0) [0|255] ""  TestTool_FO
 SG_ DTCI_DTCTriggered_786 : 0|1@0+ (1,0) [0|1] ""  TestTool_FO
 SG_ DTCI_HistStat_786 : 44|1@0+ (1,0) [0|1] ""  TestTool_FO
 SG_ DTCI_TstFldCdClrdStat_786 : 43|1@0+ (1,0) [0|1] ""  TestTool_FO
 SG_ DTCI_TstFldPwrUpSt_786 : 46|1@0+ (1,0) [0|1] ""  TestTool_FO
 SG_ DTCI_TstNPsdCdClrdSt_786 : 42|1@0+ (1,0) [0|1] ""  TestTool_FO
 SG_ DTCI_TstNPsdPwrUpSt_786 : 45|1@0+ (1,0) [0|1] ""  TestTool_FO
 SG_ DTCIUnused1_786 : 7|1@0+ (1,0) [0|1] ""  TestTool_FO
 SG_ DTCIUnused2_786 : 6|1@0+ (1,0) [0|1] ""  TestTool_FO
 SG_ DTCIUnused3_786 : 5|1@0+ (1,0) [0|1] ""  TestTool_FO
 SG_ DTCIUnused4_786 : 4|1@0+ (1,0) [0|1] ""  TestTool_FO
 SG_ DTCIUnused5_786 : 3|1@0+ (1,0) [0|1] ""  TestTool_FO
 SG_ DTCIUnused6_786 : 2|1@0+ (1,0) [0|1] ""  TestTool_FO
 SG_ DTCIUnused7_786 : 1|1@0+ (1,0) [0|1] ""  TestTool_FO
 SG_ DTCI_WrnIndRqdSt_786 : 47|1@0+ (1,0) [0|1] ""  TestTool_FO

BO_ 1928 DTC_Triggered_788_FO: 7 _DOFIMU1_FO
 SG_ DTCI_CodeSupported_788 : 40|1@0+ (1,0) [0|1] ""  TestTool_FO
 SG_ DTCI_CurrentStatus_788 : 41|1@0+ (1,0) [0|1] ""  TestTool_FO
 SG_ DTCI_DTCFailType_788 : 39|8@0+ (1,0) [0|255] ""  TestTool_FO
 SG_ DTCI_DTCFaultType_788 : 55|8@0+ (1,0) [0|255] ""  TestTool_FO
 SG_ DTCI_DTCNumber_788 : 23|16@0+ (1,0) [0|65535] ""  TestTool_FO
 SG_ DTCI_DTCSource_788 : 15|8@0+ (1,0) [0|255] ""  TestTool_FO
 SG_ DTCI_DTCTriggered_788 : 0|1@0+ (1,0) [0|1] ""  TestTool_FO
 SG_ DTCI_HistStat_788 : 44|1@0+ (1,0) [0|1] ""  TestTool_FO
 SG_ DTCI_TstFldCdClrdStat_788 : 42|1@0+ (1,0) [0|1] ""  TestTool_FO
 SG_ DTCI_TstFldPwrUpSt_788 : 46|1@0+ (1,0) [0|1] ""  TestTool_FO
 SG_ DTCI_TstNPsdCdClrdSt_788 : 43|1@0+ (1,0) [0|1] ""  TestTool_FO
 SG_ DTCI_TstNPsdPwrUpSt_788 : 45|1@0+ (1,0) [0|1] ""  TestTool_FO
 SG_ DTCIUnused1_788 : 7|1@0+ (1,0) [0|1] ""  TestTool_FO
 SG_ DTCIUnused2_788 : 6|1@0+ (1,0) [0|1] ""  TestTool_FO
 SG_ DTCIUnused3_788 : 5|1@0+ (1,0) [0|1] ""  TestTool_FO
 SG_ DTCIUnused4_788 : 4|1@0+ (1,0) [0|1] ""  TestTool_FO
 SG_ DTCIUnused5_788 : 3|1@0+ (1,0) [0|1] ""  TestTool_FO
 SG_ DTCIUnused6_788 : 2|1@0+ (1,0) [0|1] ""  TestTool_FO
 SG_ DTCIUnused7_788 : 1|1@0+ (1,0) [0|1] ""  TestTool_FO
 SG_ DTCI_WrnIndRqdSt_788 : 47|1@0+ (1,0) [0|1] ""  TestTool_FO

BO_ 1929 DTC_Triggered_789_FO: 7 _DOFIMU2_FO
 SG_ DTCI_CodeSupported_789 : 40|1@0+ (1,0) [0|1] ""  TestTool_FO
 SG_ DTCI_CurrentStatus_789 : 41|1@0+ (1,0) [0|1] ""  TestTool_FO
 SG_ DTCI_DTCFailType_789 : 39|8@0+ (1,0) [0|255] ""  TestTool_FO
 SG_ DTCI_DTCFaultType_789 : 55|8@0+ (1,0) [0|255] ""  TestTool_FO
 SG_ DTCI_DTCNumber_789 : 23|16@0+ (1,0) [0|65535] ""  TestTool_FO
 SG_ DTCI_DTCSource_789 : 15|8@0+ (1,0) [0|255] ""  TestTool_FO
 SG_ DTCI_DTCTriggered_789 : 0|1@0+ (1,0) [0|1] ""  TestTool_FO
 SG_ DTCI_HistStat_789 : 44|1@0+ (1,0) [0|1] ""  TestTool_FO
 SG_ DTCI_TstFldCdClrdStat_789 : 43|1@0+ (1,0) [0|1] ""  TestTool_FO
 SG_ DTCI_TstFldPwrUpSt_789 : 46|1@0+ (1,0) [0|1] ""  TestTool_FO
 SG_ DTCI_TstNPsdCdClrdSt_789 : 42|1@0+ (1,0) [0|1] ""  TestTool_FO
 SG_ DTCI_TstNPsdPwrUpSt_789 : 45|1@0+ (1,0) [0|1] ""  TestTool_FO
 SG_ DTCIUnused1_789 : 7|1@0+ (1,0) [0|1] ""  TestTool_FO
 SG_ DTCIUnused2_789 : 6|1@0+ (1,0) [0|1] ""  TestTool_FO
 SG_ DTCIUnused3_789 : 5|1@0+ (1,0) [0|1] ""  TestTool_FO
 SG_ DTCIUnused4_789 : 4|1@0+ (1,0) [0|1] ""  TestTool_FO
 SG_ DTCIUnused5_789 : 3|1@0+ (1,0) [0|1] ""  TestTool_FO
 SG_ DTCIUnused6_789 : 2|1@0+ (1,0) [0|1] ""  TestTool_FO
 SG_ DTCIUnused7_789 : 1|1@0+ (1,0) [0|1] ""  TestTool_FO
 SG_ DTCI_WrnIndRqdSt_789 : 47|1@0+ (1,0) [0|1] ""  TestTool_FO

BO_ 1352 UUDT_Resp_From_6DOFIMU2_FO: 8 _DOFIMU2_FO
 SG_ DgnInf : 7|64@0+ (1,0) [0|1.84467440737096E+019] ""  TestTool_FO

BO_ 588 USDT_Req_to_EOCM2B_K1_FO: 8 TestTool_FO
 SG_ DgnInf : 7|64@0+ (1,0) [0|1.84467440737096E+019] ""  EOCM2B_K1_FO

BO_ 1356 UUDT_Resp_From_EOCM2B_K1_FO: 8 EOCM2B_K1_FO
 SG_ DgnInf : 7|64@0+ (1,0) [0|1.84467440737096E+019] ""  TestTool_FO

BO_ 1612 USDT_Resp_From_EOCM2B_K1_FO: 8 EOCM2B_K1_FO
 SG_ DgnInf : 7|64@0+ (1,0) [0|1.84467440737096E+019] ""  TestTool_FO

BO_ 1616 USDT_Resp_From_EOCM2A_IMX6_FO: 8 EOCM2A_IMX6_FO
 SG_ DgnInf : 7|64@0+ (1,0) [0|1.84467440737096E+019] ""  TestTool_FO

BO_ 1360 UUDT_Resp_From_EOCM2A_IMX6_FO: 8 EOCM2A_IMX6_FO
 SG_ DgnInf : 7|64@0+ (1,0) [0|1.84467440737096E+019] ""  TestTool_FO

BO_ 592 USDT_Req_to_EOCM2A_IMX6_FO: 8 TestTool_FO
 SG_ DgnInf : 7|64@0+ (1,0) [0|1.84467440737096E+019] ""  EOCM2A_IMX6_FO

BO_ 1610 USDT_Resp_From_EOCM2A_K1_FO: 8 EOCM2A_K1_FO
 SG_ DgnInf : 7|64@0+ (1,0) [0|1.84467440737096E+019] ""  TestTool_FO

BO_ 1354 UUDT_Resp_From_EOCM2A_K1_FO: 8 EOCM2A_K1_FO
 SG_ DgnInf : 7|64@0+ (1,0) [0|1.84467440737096E+019] ""  TestTool_FO

BO_ 586 USDT_Req_to_EOCM2A_K1_FO: 8 TestTool_FO
 SG_ DgnInf : 7|64@0+ (1,0) [0|1.84467440737096E+019] ""  EOCM2A_K1_FO

BO_ 1925 DTC_Triggered_785_FO: 7 NVS_FO
 SG_ DTCI_CodeSupported_785 : 40|1@0+ (1,0) [0|1] ""  TestTool_FO
 SG_ DTCI_CurrentStatus_785 : 41|1@0+ (1,0) [0|1] ""  TestTool_FO
 SG_ DTCI_DTCFailType_785 : 39|8@0+ (1,0) [0|255] ""  TestTool_FO
 SG_ DTCI_DTCFaultType_785 : 55|8@0+ (1,0) [0|255] ""  TestTool_FO
 SG_ DTCI_DTCNumber_785 : 23|16@0+ (1,0) [0|65535] ""  TestTool_FO
 SG_ DTCI_DTCSource_785 : 15|8@0+ (1,0) [0|255] ""  TestTool_FO
 SG_ DTCI_DTCTriggered_785 : 0|1@0+ (1,0) [0|1] ""  TestTool_FO
 SG_ DTCI_HistStat_785 : 44|1@0+ (1,0) [0|1] ""  TestTool_FO
 SG_ DTCI_TstFldCdClrdStat_785 : 43|1@0+ (1,0) [0|1] ""  TestTool_FO
 SG_ DTCI_TstFldPwrUpSt_785 : 46|1@0+ (1,0) [0|1] ""  TestTool_FO
 SG_ DTCI_TstNPsdCdClrdSt_785 : 42|1@0+ (1,0) [0|1] ""  TestTool_FO
 SG_ DTCI_TstNPsdPwrUpSt_785 : 45|1@0+ (1,0) [0|1] ""  TestTool_FO
 SG_ DTCIUnused1_785 : 7|1@0+ (1,0) [0|1] ""  TestTool_FO
 SG_ DTCIUnused2_785 : 6|1@0+ (1,0) [0|1] ""  TestTool_FO
 SG_ DTCIUnused3_785 : 5|1@0+ (1,0) [0|1] ""  TestTool_FO
 SG_ DTCIUnused4_785 : 4|1@0+ (1,0) [0|1] ""  TestTool_FO
 SG_ DTCIUnused5_785 : 3|1@0+ (1,0) [0|1] ""  TestTool_FO
 SG_ DTCIUnused6_785 : 2|1@0+ (1,0) [0|1] ""  TestTool_FO
 SG_ DTCIUnused7_785 : 1|1@0+ (1,0) [0|1] ""  TestTool_FO
 SG_ DTCI_WrnIndRqdSt_785 : 47|1@0+ (1,0) [0|1] ""  TestTool_FO

BO_ 1859 VIN_Digits_10_to_17_FO: 8 EOCM_F_FO
 SG_ VehIdNmDig10_17 : 7|64@0+ (1,0) [0|1] ""  EOCM2B_IMX6_FO,EOCM2B_K2_FO,EOCM2B_K1_FO,NVS_FO

BO_ 1857 VIN_Digits_2_to_9_FO: 8 EOCM_F_FO
 SG_ VehIdNmDig2_9 : 7|64@0+ (1,0) [0|1] ""  EOCM2B_IMX6_FO,EOCM2B_K2_FO,EOCM2B_K1_FO,NVS_FO

BO_ 771 Outside_Air_Temperature_FO: 2 EOCM_F_FO
 SG_ OtsAirTmpCrValV : 0|1@0+ (1,0) [0|1] ""  NVS_FO
 SG_ OtsAirTmpCrVal : 15|8@0+ (0.5,-40) [-40|87.5] "deg C"  NVS_FO

BO_ 777 Night_Vision_System_Ped_FO: 1 NVS_FO
 SG_ NVSysStat : 3|3@0+ (1,0) [0|7] ""  EOCM2A_IMX6_FO,EOCM2A_K2_FO,EOCM2A_K1_FO,EOCM2B_IMX6_FO,EOCM2B_K2_FO,EOCM2B_K1_FO,EOCM_F_FO
 SG_ NVSysPedWrnIndReq : 7|2@0+ (1,0) [0|3] ""  EOCM2A_IMX6_FO,EOCM2A_K2_FO,EOCM2A_K1_FO,EOCM2B_IMX6_FO,EOCM2B_K2_FO,EOCM2B_K1_FO,EOCM_F_FO
 SG_ NVSysPedDetCsCrStVal : 5|2@0+ (1,0) [0|3] ""  EOCM2A_IMX6_FO,EOCM2A_K2_FO,EOCM2A_K1_FO,EOCM2B_IMX6_FO,EOCM2B_K2_FO,EOCM2B_K1_FO,EOCM_F_FO
 SG_ NVSysPedDetCstStAvl : 0|1@0+ (1,0) [0|1] ""  EOCM2A_IMX6_FO,EOCM2A_K2_FO,EOCM2A_K1_FO,EOCM2B_IMX6_FO,EOCM2B_K2_FO,EOCM2B_K1_FO,EOCM_F_FO

BO_ 607 USDT_Req_to_NVS_FO: 8 TestTool_FO
 SG_ DgnInf : 7|64@0+ (1,0) [0|1.84467440737096E+019] ""  NVS_FO

BO_ 1631 USDT_Resp_From_NVS_FO: 8 NVS_FO
 SG_ DgnInf : 7|64@0+ (1,0) [0|1.84467440737096E+019] ""  TestTool_FO

BO_ 1375 UUDT_Resp_From_NVS_FO: 8 NVS_FO
 SG_ DgnInf : 7|64@0+ (1,0) [0|1.84467440737096E+019] ""  TestTool_FO

BO_ 1540 ADAS_Position_FO: 8 AMM_FO
 SG_ AdvDrAstMpLatOffst : 40|9@0+ (1,-256) [-256|255] "m"  EOCM2B_IMX6_FO,EOCM2B_K2_FO,EOCM2B_K1_FO,EOCM2A_IMX6_FO,EOCM2A_K2_FO,EOCM2A_K1_FO
 SG_ AdvDrAstMpPstnIndx : 63|2@0+ (1,0) [0|3] ""  EOCM2B_IMX6_FO,EOCM2B_K2_FO,EOCM2B_K1_FO,EOCM2A_IMX6_FO,EOCM2A_K2_FO,EOCM2A_K1_FO
 SG_ AdvDrAstMpPstnCnf : 61|3@0+ (1,0) [0|7] ""  EOCM2B_IMX6_FO,EOCM2B_K2_FO,EOCM2B_K1_FO,EOCM2A_IMX6_FO,EOCM2A_K2_FO,EOCM2A_K1_FO
 SG_ AdvDrAstMpPsnIdxCrLn : 58|3@0+ (1,0) [0|7] ""  EOCM2B_IMX6_FO,EOCM2B_K2_FO,EOCM2B_K1_FO,EOCM2A_IMX6_FO,EOCM2A_K2_FO,EOCM2A_K1_FO
 SG_ AdvDrAstMpPstnPthIndx : 46|6@0+ (1,0) [0|63] ""  EOCM2B_IMX6_FO,EOCM2B_K2_FO,EOCM2B_K1_FO,EOCM2A_IMX6_FO,EOCM2A_K2_FO,EOCM2A_K1_FO
 SG_ AdvDrAstMpPstnProb : 31|5@0+ (3.333,0) [0|103.323] "%"  EOCM2B_IMX6_FO,EOCM2B_K2_FO,EOCM2B_K1_FO,EOCM2A_IMX6_FO,EOCM2A_K2_FO,EOCM2A_K1_FO
 SG_ AdvDrAstMpPstnCycCnt : 26|2@0+ (1,0) [0|3] ""  EOCM2B_IMX6_FO,EOCM2B_K2_FO,EOCM2B_K1_FO,EOCM2A_IMX6_FO,EOCM2A_K2_FO,EOCM2A_K1_FO
 SG_ AdvDrAstMpPstnAge : 24|9@0+ (5,0) [0|2555] "ms"  EOCM2B_IMX6_FO,EOCM2B_K2_FO,EOCM2B_K1_FO,EOCM2A_IMX6_FO,EOCM2A_K2_FO,EOCM2A_K1_FO
 SG_ AdvDrAstMpPstnRelHd : 23|8@0+ (1.417,0) [0|361.335] "deg"  EOCM2B_IMX6_FO,EOCM2B_K2_FO,EOCM2B_K1_FO,EOCM2A_IMX6_FO,EOCM2A_K2_FO,EOCM2A_K1_FO
 SG_ AdvDrAstMpPstnMsgTyp : 7|3@0+ (1,0) [0|7] ""  EOCM2B_IMX6_FO,EOCM2B_K2_FO,EOCM2B_K1_FO,EOCM2A_IMX6_FO,EOCM2A_K2_FO,EOCM2A_K1_FO
 SG_ AdvDrAstMpPstnOfst : 4|13@0+ (1,0) [0|8191] "m"  EOCM2B_IMX6_FO,EOCM2B_K2_FO,EOCM2B_K1_FO,EOCM2A_IMX6_FO,EOCM2A_K2_FO,EOCM2A_K1_FO

BO_ 1608 USDT_Resp_From_6DOFIMU2_FO: 8 _DOFIMU2_FO
 SG_ DgnInf : 7|64@0+ (1,0) [0|1.84467440737096E+019] ""  TestTool_FO

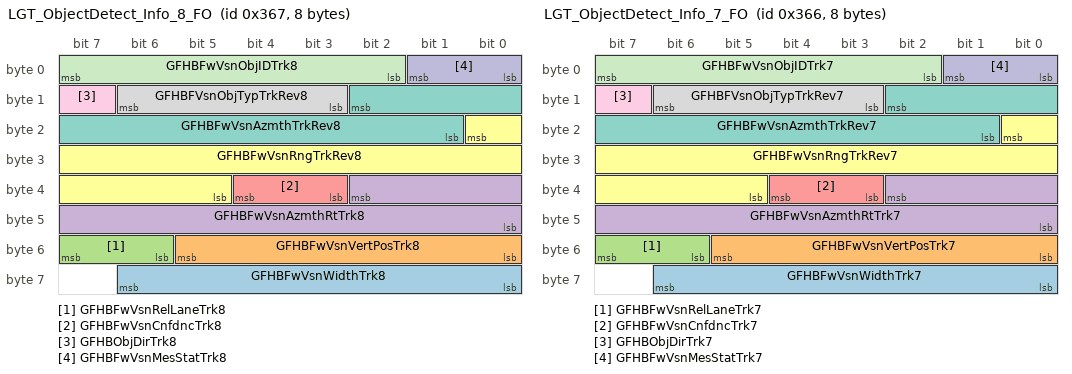
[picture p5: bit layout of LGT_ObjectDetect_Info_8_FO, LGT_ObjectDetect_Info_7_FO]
BO_ 871 LGT_ObjectDetect_Info_8_FO: 8 VIS2_FO
 SG_ GFHBFwVsnWidthTrk8 : 62|7@0+ (0.1,0) [0|12.7] "deg"  EOCM_F_FO
 SG_ GFHBFwVsnVertPosTrk8 : 53|6@0+ (0.25,-3) [-3|12.75] "deg"  EOCM_F_FO
 SG_ GFHBFwVsnRelLaneTrk8 : 55|2@0+ (1,0) [0|3] ""  EOCM_F_FO
 SG_ GFHBFwVsnAzmthRtTrk8 : 34|11@0- (0.125,0) [-128|127.875] "deg/s"  EOCM_F_FO
 SG_ GFHBFwVsnCnfdncTrk8 : 36|2@0+ (1,0) [0|3] ""  EOCM_F_FO
 SG_ GFHBFwVsnRngTrkRev8 : 16|12@0+ (0.2,0) [0|819] "m"  EOCM_F_FO
 SG_ GFHBFwVsnAzmthTrkRev8 : 10|10@0- (0.05,0) [-25.6|25.55] "deg"  EOCM_F_FO
 SG_ GFHBFVsnObjTypTrkRev8 : 14|4@0+ (1,0) [0|15] ""  EOCM_F_FO
 SG_ GFHBObjDirTrk8 : 15|1@0+ (1,0) [0|1] ""  EOCM_F_FO
 SG_ GFHBFwVsnMesStatTrk8 : 1|2@0+ (1,0) [0|3] ""  EOCM_F_FO
 SG_ GFHBFwVsnObjIDTrk8 : 7|6@0+ (1,0) [0|63] ""  EOCM_F_FO

BO_ 870 LGT_ObjectDetect_Info_7_FO: 8 VIS2_FO
 SG_ GFHBFwVsnWidthTrk7 : 62|7@0+ (0.1,0) [0|12.7] "deg"  EOCM_F_FO
 SG_ GFHBFwVsnVertPosTrk7 : 53|6@0+ (0.25,-3) [-3|12.75] "deg"  EOCM_F_FO
 SG_ GFHBFwVsnRelLaneTrk7 : 55|2@0+ (1,0) [0|3] ""  EOCM_F_FO
 SG_ GFHBFwVsnAzmthRtTrk7 : 34|11@0- (0.125,0) [-128|127.875] "deg/s"  EOCM_F_FO
 SG_ GFHBFwVsnCnfdncTrk7 : 36|2@0+ (1,0) [0|3] ""  EOCM_F_FO
 SG_ GFHBFwVsnRngTrkRev7 : 16|12@0+ (0.2,0) [0|819] "m"  EOCM_F_FO
 SG_ GFHBFwVsnAzmthTrkRev7 : 10|10@0- (0.05,0) [-25.6|25.55] "deg"  EOCM_F_FO
 SG_ GFHBFVsnObjTypTrkRev7 : 14|4@0+ (1,0) [0|15] ""  EOCM_F_FO
 SG_ GFHBObjDirTrk7 : 15|1@0+ (1,0) [0|1] ""  EOCM_F_FO
 SG_ GFHBFwVsnMesStatTrk7 : 1|2@0+ (1,0) [0|3] ""  EOCM_F_FO
 SG_ GFHBFwVsnObjIDTrk7 : 7|6@0+ (1,0) [0|63] ""  EOCM_F_FO

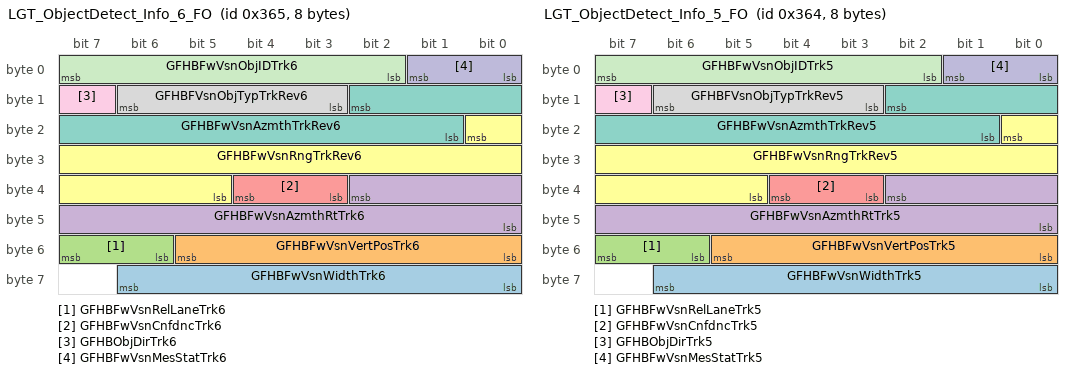
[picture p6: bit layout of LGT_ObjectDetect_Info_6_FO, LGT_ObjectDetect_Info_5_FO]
BO_ 869 LGT_ObjectDetect_Info_6_FO: 8 VIS2_FO
 SG_ GFHBFwVsnWidthTrk6 : 62|7@0+ (0.1,0) [0|12.7] "deg"  EOCM_F_FO
 SG_ GFHBFwVsnVertPosTrk6 : 53|6@0+ (0.25,-3) [-3|12.75] "deg"  EOCM_F_FO
 SG_ GFHBFwVsnRelLaneTrk6 : 55|2@0+ (1,0) [0|3] ""  EOCM_F_FO
 SG_ GFHBFwVsnAzmthRtTrk6 : 34|11@0- (0.125,0) [-128|127.875] "deg/s"  EOCM_F_FO
 SG_ GFHBFwVsnCnfdncTrk6 : 36|2@0+ (1,0) [0|3] ""  EOCM_F_FO
 SG_ GFHBFwVsnRngTrkRev6 : 16|12@0+ (0.2,0) [0|819] "m"  EOCM_F_FO
 SG_ GFHBFwVsnAzmthTrkRev6 : 10|10@0- (0.05,0) [-25.6|25.55] "deg"  EOCM_F_FO
 SG_ GFHBFVsnObjTypTrkRev6 : 14|4@0+ (1,0) [0|15] ""  EOCM_F_FO
 SG_ GFHBObjDirTrk6 : 15|1@0+ (1,0) [0|1] ""  EOCM_F_FO
 SG_ GFHBFwVsnMesStatTrk6 : 1|2@0+ (1,0) [0|3] ""  EOCM_F_FO
 SG_ GFHBFwVsnObjIDTrk6 : 7|6@0+ (1,0) [0|63] ""  EOCM_F_FO

BO_ 868 LGT_ObjectDetect_Info_5_FO: 8 VIS2_FO
 SG_ GFHBFwVsnWidthTrk5 : 62|7@0+ (0.1,0) [0|12.7] "deg"  EOCM_F_FO
 SG_ GFHBFwVsnVertPosTrk5 : 53|6@0+ (0.25,-3) [-3|12.75] "deg"  EOCM_F_FO
 SG_ GFHBFwVsnRelLaneTrk5 : 55|2@0+ (1,0) [0|3] ""  EOCM_F_FO
 SG_ GFHBFwVsnAzmthRtTrk5 : 34|11@0- (0.125,0) [-128|127.875] "deg/s"  EOCM_F_FO
 SG_ GFHBFwVsnCnfdncTrk5 : 36|2@0+ (1,0) [0|3] ""  EOCM_F_FO
 SG_ GFHBFwVsnRngTrkRev5 : 16|12@0+ (0.2,0) [0|819] "m"  EOCM_F_FO
 SG_ GFHBFwVsnAzmthTrkRev5 : 10|10@0- (0.05,0) [-25.6|25.55] "deg"  EOCM_F_FO
 SG_ GFHBFVsnObjTypTrkRev5 : 14|4@0+ (1,0) [0|15] ""  EOCM_F_FO
 SG_ GFHBObjDirTrk5 : 15|1@0+ (1,0) [0|1] ""  EOCM_F_FO
 SG_ GFHBFwVsnMesStatTrk5 : 1|2@0+ (1,0) [0|3] ""  EOCM_F_FO
 SG_ GFHBFwVsnObjIDTrk5 : 7|6@0+ (1,0) [0|63] ""  EOCM_F_FO

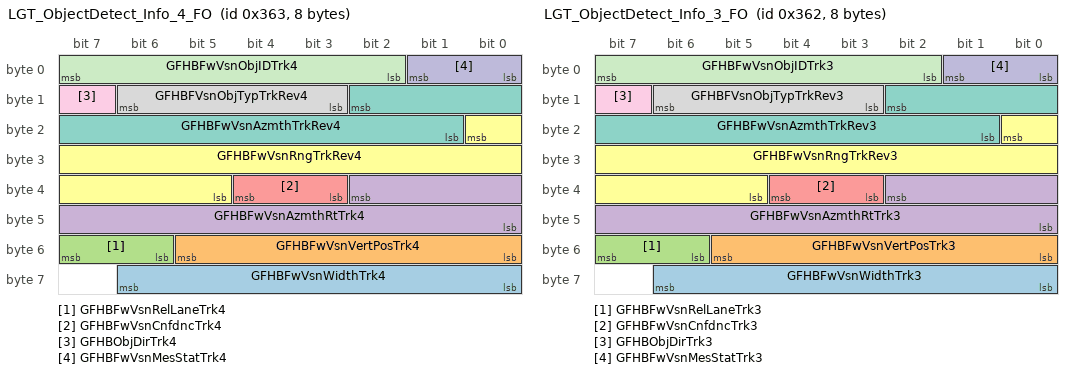
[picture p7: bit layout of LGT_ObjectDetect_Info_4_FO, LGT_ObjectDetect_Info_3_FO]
BO_ 867 LGT_ObjectDetect_Info_4_FO: 8 VIS2_FO
 SG_ GFHBFwVsnWidthTrk4 : 62|7@0+ (0.1,0) [0|12.7] "deg"  EOCM_F_FO
 SG_ GFHBFwVsnVertPosTrk4 : 53|6@0+ (0.25,-3) [-3|12.75] "deg"  EOCM_F_FO
 SG_ GFHBFwVsnRelLaneTrk4 : 55|2@0+ (1,0) [0|3] ""  EOCM_F_FO
 SG_ GFHBFwVsnAzmthRtTrk4 : 34|11@0- (0.125,0) [-128|127.875] "deg/s"  EOCM_F_FO
 SG_ GFHBFwVsnCnfdncTrk4 : 36|2@0+ (1,0) [0|3] ""  EOCM_F_FO
 SG_ GFHBFwVsnRngTrkRev4 : 16|12@0+ (0.2,0) [0|819] "m"  EOCM_F_FO
 SG_ GFHBFwVsnAzmthTrkRev4 : 10|10@0- (0.05,0) [-25.6|25.55] "deg"  EOCM_F_FO
 SG_ GFHBFVsnObjTypTrkRev4 : 14|4@0+ (1,0) [0|15] ""  EOCM_F_FO
 SG_ GFHBObjDirTrk4 : 15|1@0+ (1,0) [0|1] ""  EOCM_F_FO
 SG_ GFHBFwVsnMesStatTrk4 : 1|2@0+ (1,0) [0|3] ""  EOCM_F_FO
 SG_ GFHBFwVsnObjIDTrk4 : 7|6@0+ (1,0) [0|63] ""  EOCM_F_FO

BO_ 866 LGT_ObjectDetect_Info_3_FO: 8 VIS2_FO
 SG_ GFHBFwVsnWidthTrk3 : 62|7@0+ (0.1,0) [0|12.7] "deg"  EOCM_F_FO
 SG_ GFHBFwVsnVertPosTrk3 : 53|6@0+ (0.25,-3) [-3|12.75] "deg"  EOCM_F_FO
 SG_ GFHBFwVsnRelLaneTrk3 : 55|2@0+ (1,0) [0|3] ""  EOCM_F_FO
 SG_ GFHBFwVsnAzmthRtTrk3 : 34|11@0- (0.125,0) [-128|127.875] "deg/s"  EOCM_F_FO
 SG_ GFHBFwVsnCnfdncTrk3 : 36|2@0+ (1,0) [0|3] ""  EOCM_F_FO
 SG_ GFHBFwVsnRngTrkRev3 : 16|12@0+ (0.2,0) [0|819] "m"  EOCM_F_FO
 SG_ GFHBFwVsnAzmthTrkRev3 : 10|10@0- (0.05,0) [-25.6|25.55] "deg"  EOCM_F_FO
 SG_ GFHBFVsnObjTypTrkRev3 : 14|4@0+ (1,0) [0|15] ""  EOCM_F_FO
 SG_ GFHBObjDirTrk3 : 15|1@0+ (1,0) [0|1] ""  EOCM_F_FO
 SG_ GFHBFwVsnMesStatTrk3 : 1|2@0+ (1,0) [0|3] ""  EOCM_F_FO
 SG_ GFHBFwVsnObjIDTrk3 : 7|6@0+ (1,0) [0|63] ""  EOCM_F_FO

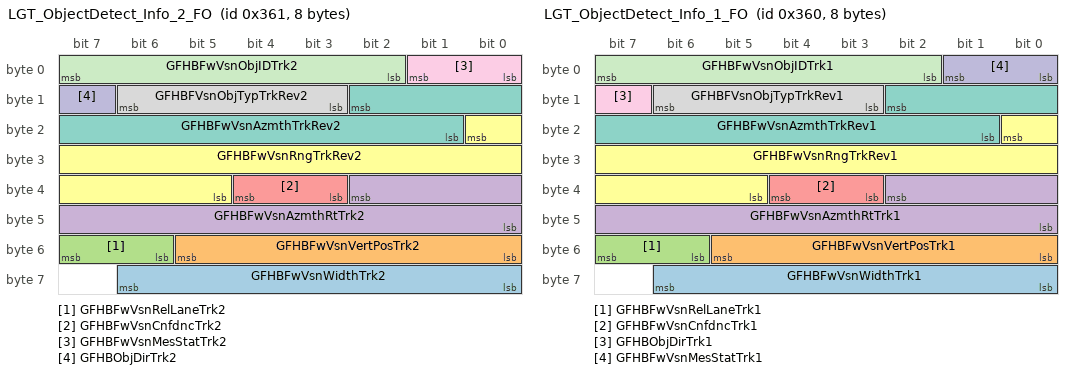
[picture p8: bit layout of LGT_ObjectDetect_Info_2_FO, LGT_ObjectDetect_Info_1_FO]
BO_ 865 LGT_ObjectDetect_Info_2_FO: 8 VIS2_FO
 SG_ GFHBFwVsnWidthTrk2 : 62|7@0+ (0.1,0) [0|12.7] "deg"  EOCM_F_FO
 SG_ GFHBFwVsnVertPosTrk2 : 53|6@0+ (0.25,-3) [-3|12.75] "deg"  EOCM_F_FO
 SG_ GFHBFwVsnRelLaneTrk2 : 55|2@0+ (1,0) [0|3] ""  EOCM_F_FO
 SG_ GFHBFwVsnAzmthRtTrk2 : 34|11@0- (0.125,0) [-128|127.875] "deg/s"  EOCM_F_FO
 SG_ GFHBFwVsnCnfdncTrk2 : 36|2@0+ (1,0) [0|3] ""  EOCM_F_FO
 SG_ GFHBFwVsnRngTrkRev2 : 16|12@0+ (0.2,0) [0|819] "m"  EOCM_F_FO
 SG_ GFHBFwVsnAzmthTrkRev2 : 10|10@0- (0.05,0) [-25.6|25.55] "deg"  EOCM_F_FO
 SG_ GFHBFVsnObjTypTrkRev2 : 14|4@0+ (1,0) [0|15] ""  EOCM_F_FO
 SG_ GFHBFwVsnMesStatTrk2 : 1|2@0+ (1,0) [0|3] ""  EOCM_F_FO
 SG_ GFHBObjDirTrk2 : 15|1@0+ (1,0) [0|1] ""  EOCM_F_FO
 SG_ GFHBFwVsnObjIDTrk2 : 7|6@0+ (1,0) [0|63] ""  EOCM_F_FO

BO_ 864 LGT_ObjectDetect_Info_1_FO: 8 VIS2_FO
 SG_ GFHBFwVsnWidthTrk1 : 62|7@0+ (0.1,0) [0|12.7] "deg"  EOCM_F_FO
 SG_ GFHBFwVsnVertPosTrk1 : 53|6@0+ (0.25,-3) [-3|12.75] "deg"  EOCM_F_FO
 SG_ GFHBFwVsnRelLaneTrk1 : 55|2@0+ (1,0) [0|3] ""  EOCM_F_FO
 SG_ GFHBFwVsnAzmthRtTrk1 : 34|11@0- (0.125,0) [-128|127.875] "deg/s"  EOCM_F_FO
 SG_ GFHBFwVsnCnfdncTrk1 : 36|2@0+ (1,0) [0|3] ""  EOCM_F_FO
 SG_ GFHBFwVsnRngTrkRev1 : 16|12@0+ (0.2,0) [0|819] "m"  EOCM_F_FO
 SG_ GFHBFwVsnAzmthTrkRev1 : 10|10@0- (0.05,0) [-25.6|25.55] "deg"  EOCM_F_FO
 SG_ GFHBFVsnObjTypTrkRev1 : 14|4@0+ (1,0) [0|15] ""  EOCM_F_FO
 SG_ GFHBObjDirTrk1 : 15|1@0+ (1,0) [0|1] ""  EOCM_F_FO
 SG_ GFHBFwVsnMesStatTrk1 : 1|2@0+ (1,0) [0|3] ""  EOCM_F_FO
 SG_ GFHBFwVsnObjIDTrk1 : 7|6@0+ (1,0) [0|63] ""  EOCM_F_FO

BO_ 1915 DTC_Triggered_77B_FO: 7 VIS_FO
 SG_ DTCI_DTCFaultType_77B : 55|8@0+ (1,0) [0|255] ""  TestTool_FO
 SG_ DTCI_CodeSupported_77B : 40|1@0+ (1,0) [0|1] ""  TestTool_FO
 SG_ DTCI_CurrentStatus_77B : 41|1@0+ (1,0) [0|1] ""  TestTool_FO
 SG_ DTCI_TstNPsdCdClrdSt_77B : 42|1@0+ (1,0) [0|1] ""  TestTool_FO
 SG_ DTCI_TstFldCdClrdStat_77B : 43|1@0+ (1,0) [0|1] ""  TestTool_FO
 SG_ DTCI_HistStat_77B : 44|1@0+ (1,0) [0|1] ""  TestTool_FO
 SG_ DTCI_TstNPsdPwrUpSt_77B : 45|1@0+ (1,0) [0|1] ""  TestTool_FO
 SG_ DTCI_TstFldPwrUpSt_77B : 46|1@0+ (1,0) [0|1] ""  TestTool_FO
 SG_ DTCI_WrnIndRqdSt_77B : 47|1@0+ (1,0) [0|1] ""  TestTool_FO
 SG_ DTCI_DTCFailType_77B : 39|8@0+ (1,0) [0|255] ""  TestTool_FO
 SG_ DTCI_DTCNumber_77B : 23|16@0+ (1,0) [0|65535] ""  TestTool_FO
 SG_ DTCI_DTCSource_77B : 15|8@0+ (1,0) [0|255] ""  TestTool_FO
 SG_ DTCI_DTCTriggered_77B : 0|1@0+ (1,0) [0|1] ""  TestTool_FO
 SG_ DTCIUnused7_77B : 1|1@0+ (1,0) [0|1] ""  TestTool_FO
 SG_ DTCIUnused6_77B : 2|1@0+ (1,0) [0|1] ""  TestTool_FO
 SG_ DTCIUnused5_77B : 3|1@0+ (1,0) [0|1] ""  TestTool_FO
 SG_ DTCIUnused4_77B : 4|1@0+ (1,0) [0|1] ""  TestTool_FO
 SG_ DTCIUnused3_77B : 5|1@0+ (1,0) [0|1] ""  TestTool_FO
 SG_ DTCIUnused2_77B : 6|1@0+ (1,0) [0|1] ""  TestTool_FO
 SG_ DTCIUnused1_77B : 7|1@0+ (1,0) [0|1] ""  TestTool_FO

BO_ 1923 DTC_Triggered_783_FO: 7 RSRR_FO
 SG_ DTCI_WrnIndRqdSt_783 : 47|1@0+ (1,0) [0|1] ""  TestTool_FO
 SG_ DTCI_TstNPsdPwrUpSt_783 : 45|1@0+ (1,0) [0|1] ""  TestTool_FO
 SG_ DTCI_TstNPsdCdClrdSt_783 : 42|1@0+ (1,0) [0|1] ""  TestTool_FO
 SG_ DTCI_TstFldPwrUpSt_783 : 46|1@0+ (1,0) [0|1] ""  TestTool_FO
 SG_ DTCI_TstFldCdClrdStat_783 : 43|1@0+ (1,0) [0|1] ""  TestTool_FO
 SG_ DTCI_HistStat_783 : 44|1@0+ (1,0) [0|1] ""  TestTool_FO
 SG_ DTCI_DTCTriggered_783 : 0|1@0+ (1,0) [0|1] ""  TestTool_FO
 SG_ DTCI_DTCSource_783 : 15|8@0+ (1,0) [0|255] ""  TestTool_FO
 SG_ DTCI_DTCNumber_783 : 23|16@0+ (1,0) [0|65535] ""  TestTool_FO
 SG_ DTCI_DTCFaultType_783 : 55|8@0+ (1,0) [0|255] ""  TestTool_FO
 SG_ DTCI_DTCFailType_783 : 39|8@0+ (1,0) [0|255] ""  TestTool_FO
 SG_ DTCI_CurrentStatus_783 : 41|1@0+ (1,0) [0|1] ""  TestTool_FO
 SG_ DTCI_CodeSupported_783 : 40|1@0+ (1,0) [0|1] ""  TestTool_FO
 SG_ DTCIUnused7_783 : 1|1@0+ (1,0) [0|1] ""  TestTool_FO
 SG_ DTCIUnused6_783 : 2|1@0+ (1,0) [0|1] ""  TestTool_FO
 SG_ DTCIUnused5_783 : 3|1@0+ (1,0) [0|1] ""  TestTool_FO
 SG_ DTCIUnused4_783 : 4|1@0+ (1,0) [0|1] ""  TestTool_FO
 SG_ DTCIUnused3_783 : 5|1@0+ (1,0) [0|1] ""  TestTool_FO
 SG_ DTCIUnused2_783 : 6|1@0+ (1,0) [0|1] ""  TestTool_FO
 SG_ DTCIUnused1_783 : 7|1@0+ (1,0) [0|1] ""  TestTool_FO

BO_ 1924 DTC_Triggered_784_FO: 7 RRSRR_FO
 SG_ DTCI_HistStat_784 : 44|1@0+ (1,0) [0|1] ""  TestTool_FO
 SG_ DTCI_TstFldCdClrdStat_784 : 43|1@0+ (1,0) [0|1] ""  TestTool_FO
 SG_ DTCI_TstFldPwrUpSt_784 : 46|1@0+ (1,0) [0|1] ""  TestTool_FO
 SG_ DTCI_TstNPsdCdClrdSt_784 : 42|1@0+ (1,0) [0|1] ""  TestTool_FO
 SG_ DTCI_TstNPsdPwrUpSt_784 : 45|1@0+ (1,0) [0|1] ""  TestTool_FO
 SG_ DTCIUnused1_784 : 7|1@0+ (1,0) [0|1] ""  TestTool_FO
 SG_ DTCIUnused2_784 : 6|1@0+ (1,0) [0|1] ""  TestTool_FO
 SG_ DTCIUnused3_784 : 5|1@0+ (1,0) [0|1] ""  TestTool_FO
 SG_ DTCIUnused4_784 : 4|1@0+ (1,0) [0|1] ""  TestTool_FO
 SG_ DTCIUnused5_784 : 3|1@0+ (1,0) [0|1] ""  TestTool_FO
 SG_ DTCIUnused6_784 : 2|1@0+ (1,0) [0|1] ""  TestTool_FO
 SG_ DTCIUnused7_784 : 1|1@0+ (1,0) [0|1] ""  TestTool_FO
 SG_ DTCI_WrnIndRqdSt_784 : 47|1@0+ (1,0) [0|1] ""  TestTool_FO
 SG_ DTCI_CodeSupported_784 : 40|1@0+ (1,0) [0|1] ""  TestTool_FO
 SG_ DTCI_CurrentStatus_784 : 41|1@0+ (1,0) [0|1] ""  TestTool_FO
 SG_ DTCI_DTCFailType_784 : 39|8@0+ (1,0) [0|255] ""  TestTool_FO
 SG_ DTCI_DTCFaultType_784 : 55|8@0+ (1,0) [0|255] ""  TestTool_FO
 SG_ DTCI_DTCNumber_784 : 23|16@0+ (1,0) [0|65535] ""  TestTool_FO
 SG_ DTCI_DTCSource_784 : 15|8@0+ (1,0) [0|255] ""  TestTool_FO
 SG_ DTCI_DTCTriggered_784 : 0|1@0+ (1,0) [0|1] ""  TestTool_FO

BO_ 1922 DTC_Triggered_782_FO: 7 RFSRR_FO
 SG_ DTCI_WrnIndRqdSt_782 : 47|1@0+ (1,0) [0|1] ""  TestTool_FO
 SG_ DTCIUnused7_782 : 1|1@0+ (1,0) [0|1] ""  TestTool_FO
 SG_ DTCIUnused6_782 : 2|1@0+ (1,0) [0|1] ""  TestTool_FO
 SG_ DTCIUnused5_782 : 3|1@0+ (1,0) [0|1] ""  TestTool_FO
 SG_ DTCIUnused4_782 : 4|1@0+ (1,0) [0|1] ""  TestTool_FO
 SG_ DTCIUnused3_782 : 5|1@0+ (1,0) [0|1] ""  TestTool_FO
 SG_ DTCIUnused2_782 : 6|1@0+ (1,0) [0|1] ""  TestTool_FO
 SG_ DTCIUnused1_782 : 7|1@0+ (1,0) [0|1] ""  TestTool_FO
 SG_ DTCI_TstNPsdPwrUpSt_782 : 45|1@0+ (1,0) [0|1] ""  TestTool_FO
 SG_ DTCI_TstNPsdCdClrdSt_782 : 42|1@0+ (1,0) [0|1] ""  TestTool_FO
 SG_ DTCI_TstFldPwrUpSt_782 : 46|1@0+ (1,0) [0|1] ""  TestTool_FO
 SG_ DTCI_TstFldCdClrdStat_782 : 43|1@0+ (1,0) [0|1] ""  TestTool_FO
 SG_ DTCI_HistStat_782 : 44|1@0+ (1,0) [0|1] ""  TestTool_FO
 SG_ DTCI_DTCTriggered_782 : 0|1@0+ (1,0) [0|1] ""  TestTool_FO
 SG_ DTCI_DTCSource_782 : 15|8@0+ (1,0) [0|255] ""  TestTool_FO
 SG_ DTCI_DTCNumber_782 : 23|16@0+ (1,0) [0|65535] ""  TestTool_FO
 SG_ DTCI_DTCFaultType_782 : 55|8@0+ (1,0) [0|255] ""  TestTool_FO
 SG_ DTCI_DTCFailType_782 : 39|8@0+ (1,0) [0|255] ""  TestTool_FO
 SG_ DTCI_CurrentStatus_782 : 41|1@0+ (1,0) [0|1] ""  TestTool_FO
 SG_ DTCI_CodeSupported_782 : 40|1@0+ (1,0) [0|1] ""  TestTool_FO

BO_ 1920 DTC_Triggered_780_FO: 7 LRR_FO
 SG_ DTCI_CurrentStatus_780 : 41|1@0+ (1,0) [0|1] ""  TestTool_FO
 SG_ DTCI_WrnIndRqdSt_780 : 47|1@0+ (1,0) [0|1] ""  TestTool_FO
 SG_ DTCIUnused7_780 : 1|1@0+ (1,0) [0|1] ""  TestTool_FO
 SG_ DTCIUnused6_780 : 2|1@0+ (1,0) [0|1] ""  TestTool_FO
 SG_ DTCIUnused5_780 : 3|1@0+ (1,0) [0|1] ""  TestTool_FO
 SG_ DTCIUnused4_780 : 4|1@0+ (1,0) [0|1] ""  TestTool_FO
 SG_ DTCIUnused3_780 : 5|1@0+ (1,0) [0|1] ""  TestTool_FO
 SG_ DTCIUnused2_780 : 6|1@0+ (1,0) [0|1] ""  TestTool_FO
 SG_ DTCIUnused1_780 : 7|1@0+ (1,0) [0|1] ""  TestTool_FO
 SG_ DTCI_TstNPsdPwrUpSt_780 : 45|1@0+ (1,0) [0|1] ""  TestTool_FO
 SG_ DTCI_TstNPsdCdClrdSt_780 : 42|1@0+ (1,0) [0|1] ""  TestTool_FO
 SG_ DTCI_TstFldPwrUpSt_780 : 46|1@0+ (1,0) [0|1] ""  TestTool_FO
 SG_ DTCI_TstFldCdClrdStat_780 : 43|1@0+ (1,0) [0|1] ""  TestTool_FO
 SG_ DTCI_HistStat_780 : 44|1@0+ (1,0) [0|1] ""  TestTool_FO
 SG_ DTCI_DTCTriggered_780 : 0|1@0+ (1,0) [0|1] ""  TestTool_FO
 SG_ DTCI_DTCSource_780 : 15|8@0+ (1,0) [0|255] ""  TestTool_FO
 SG_ DTCI_DTCNumber_780 : 23|16@0+ (1,0) [0|65535] ""  TestTool_FO
 SG_ DTCI_DTCFaultType_780 : 55|8@0+ (1,0) [0|255] ""  TestTool_FO
 SG_ DTCI_DTCFailType_780 : 39|8@0+ (1,0) [0|255] ""  TestTool_FO
 SG_ DTCI_CodeSupported_780 : 40|1@0+ (1,0) [0|1] ""  TestTool_FO

BO_ 1921 DTC_Triggered_781_FO: 7 LFSRR_FO
 SG_ DTCI_CurrentStatus_781 : 41|1@0+ (1,0) [0|1] ""  TestTool_FO
 SG_ DTCI_WrnIndRqdSt_781 : 47|1@0+ (1,0) [0|1] ""  TestTool_FO
 SG_ DTCIUnused7_781 : 1|1@0+ (1,0) [0|1] ""  TestTool_FO
 SG_ DTCIUnused6_781 : 2|1@0+ (1,0) [0|1] ""  TestTool_FO
 SG_ DTCIUnused5_781 : 3|1@0+ (1,0) [0|1] ""  TestTool_FO
 SG_ DTCIUnused4_781 : 4|1@0+ (1,0) [0|1] ""  TestTool_FO
 SG_ DTCIUnused3_781 : 5|1@0+ (1,0) [0|1] ""  TestTool_FO
 SG_ DTCIUnused2_781 : 6|1@0+ (1,0) [0|1] ""  TestTool_FO
 SG_ DTCIUnused1_781 : 7|1@0+ (1,0) [0|1] ""  TestTool_FO
 SG_ DTCI_TstNPsdPwrUpSt_781 : 45|1@0+ (1,0) [0|1] ""  TestTool_FO
 SG_ DTCI_TstNPsdCdClrdSt_781 : 42|1@0+ (1,0) [0|1] ""  TestTool_FO
 SG_ DTCI_TstFldPwrUpSt_781 : 46|1@0+ (1,0) [0|1] ""  TestTool_FO
 SG_ DTCI_TstFldCdClrdStat_781 : 43|1@0+ (1,0) [0|1] ""  TestTool_FO
 SG_ DTCI_HistStat_781 : 44|1@0+ (1,0) [0|1] ""  TestTool_FO
 SG_ DTCI_DTCTriggered_781 : 0|1@0+ (1,0) [0|1] ""  TestTool_FO
 SG_ DTCI_DTCSource_781 : 15|8@0+ (1,0) [0|255] ""  TestTool_FO
 SG_ DTCI_DTCNumber_781 : 23|16@0+ (1,0) [0|65535] ""  TestTool_FO
 SG_ DTCI_DTCFaultType_781 : 55|8@0+ (1,0) [0|255] ""  TestTool_FO
 SG_ DTCI_DTCFailType_781 : 39|8@0+ (1,0) [0|255] ""  TestTool_FO
 SG_ DTCI_CodeSupported_781 : 40|1@0+ (1,0) [0|1] ""  TestTool_FO

BO_ 1034 Curvature_Right_Line_FO: 7 VIS2_FO
 SG_ CRL_Cnfdnc : 50|3@0+ (1,0) [0|7] ""  EOCM2A_IMX6_FO,EOCM2A_K2_FO,EOCM2A_K1_FO,EOCM_F_FO,EOCM2B_IMX6_FO,EOCM2B_K2_FO,EOCM2B_K1_FO
 SG_ CRL_ViewRng : 33|15@0+ (0.0039064,0) [0|128.0010088] "m"  EOCM2A_IMX6_FO,EOCM2A_K2_FO,EOCM2A_K1_FO,EOCM_F_FO,EOCM2B_IMX6_FO,EOCM2B_K2_FO,EOCM2B_K1_FO
 SG_ CRL_CoefdA : 17|16@0- (3.6622E-009,0) [-0.0001200029696|0.0001199993074] "1/m^2"  EOCM2A_IMX6_FO,EOCM2A_K2_FO,EOCM2A_K1_FO,EOCM_F_FO,EOCM2B_IMX6_FO,EOCM2B_K2_FO,EOCM2B_K1_FO
 SG_ CRL_CoefA : 1|16@0- (6.1036E-007,0) [-0.02000027648|0.01999966612] "1/m"  EOCM2A_IMX6_FO,EOCM2A_K2_FO,EOCM2A_K1_FO,EOCM_F_FO,EOCM2B_IMX6_FO,EOCM2B_K2_FO,EOCM2B_K1_FO

BO_ 1033 Curvature_Left_Line_FO: 7 VIS2_FO
 SG_ CLL_Cnfdnc : 50|3@0+ (1,0) [0|7] ""  EOCM2A_IMX6_FO,EOCM2A_K2_FO,EOCM2A_K1_FO,EOCM_F_FO,EOCM2B_IMX6_FO,EOCM2B_K2_FO,EOCM2B_K1_FO
 SG_ CLL_ViewRng : 33|15@0+ (0.0039064,0) [0|128.0010088] "m"  EOCM2A_IMX6_FO,EOCM2A_K2_FO,EOCM2A_K1_FO,EOCM_F_FO,EOCM2B_IMX6_FO,EOCM2B_K2_FO,EOCM2B_K1_FO
 SG_ CLL_CoefdA : 17|16@0- (3.6622E-009,0) [-0.0001200029696|0.0001199993074] "1/m^2"  EOCM2A_IMX6_FO,EOCM2A_K2_FO,EOCM2A_K1_FO,EOCM_F_FO,EOCM2B_IMX6_FO,EOCM2B_K2_FO,EOCM2B_K1_FO
 SG_ CLL_CoefA : 1|16@0- (6.1036E-007,0) [-0.02000027648|0.01999966612] "1/m"  EOCM2A_IMX6_FO,EOCM2A_K2_FO,EOCM2A_K1_FO,EOCM_F_FO,EOCM2B_IMX6_FO,EOCM2B_K2_FO,EOCM2B_K1_FO

BO_ 1365 UUDT_Resp_From_VIS2_FO: 8 VIS2_FO
 SG_ DgnInf_OBJ555 : 7|64@0+ (1,0) [0|1.84467440737096E+019] ""  TestTool_FO

BO_ 1621 USDT_Resp_From_VIS2_FO: 8 VIS2_FO
 SG_ DgnInf_OBJ655 : 7|64@0+ (1,0) [0|1.84467440737096E+019] ""  TestTool_FO

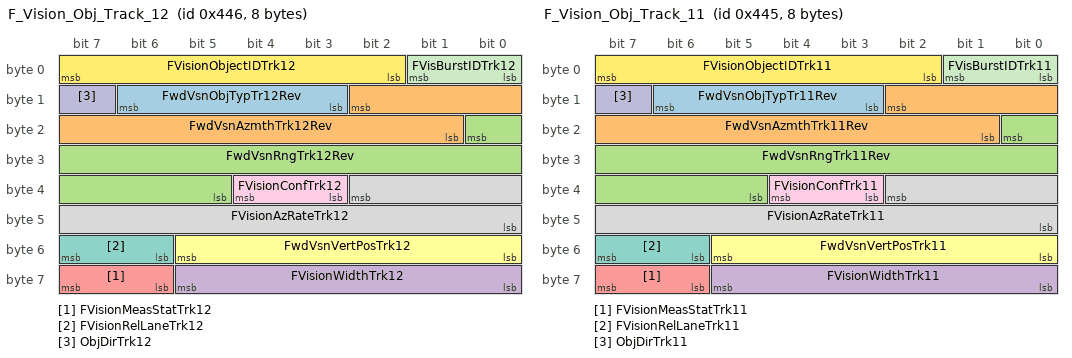
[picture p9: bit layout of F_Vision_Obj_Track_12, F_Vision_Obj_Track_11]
BO_ 1094 F_Vision_Obj_Track_12: 8 VIS2_FO
 SG_ FwdVsnObjTypTr12Rev : 14|4@0+ (1,0) [0|15] ""  EOCM_F_FO
 SG_ FwdVsnAzmthTrk12Rev : 10|10@0- (0.1,0) [-51.2|51.1] "deg"  EOCM_F_FO
 SG_ FwdVsnRngTrk12Rev : 16|12@0+ (0.1,0) [0|409.5] "m"  EOCM_F_FO
 SG_ FVisionWidthTrk12 : 61|6@0+ (0.25,0) [0|15.75] "m"  EOCM_F_FO
 SG_ FVisionMeasStatTrk12 : 63|2@0+ (1,0) [0|3] ""  EOCM_F_FO
 SG_ FwdVsnVertPosTrk12 : 53|6@0+ (0.25,-2) [-2|13.75] "deg"  EOCM_F_FO
 SG_ FVisionRelLaneTrk12 : 55|2@0+ (1,0) [0|3] ""  EOCM_F_FO
 SG_ FVisionAzRateTrk12 : 34|11@0- (0.125,0) [-128|127.875] "deg/sec"  EOCM_F_FO
 SG_ FVisionConfTrk12 : 36|2@0+ (1,0) [0|3] ""  EOCM_F_FO
 SG_ ObjDirTrk12 : 15|1@0+ (1,0) [0|1] ""  EOCM_F_FO
 SG_ FVisBurstIDTrk12 : 1|2@0+ (1,0) [0|3] ""  EOCM_F_FO
 SG_ FVisionObjectIDTrk12 : 7|6@0+ (1,0) [0|63] ""  EOCM_F_FO

BO_ 1093 F_Vision_Obj_Track_11: 8 VIS2_FO
 SG_ FwdVsnObjTypTr11Rev : 14|4@0+ (1,0) [0|15] ""  EOCM_F_FO
 SG_ FwdVsnAzmthTrk11Rev : 10|10@0- (0.1,0) [-51.2|51.1] "deg"  EOCM_F_FO
 SG_ FwdVsnRngTrk11Rev : 16|12@0+ (0.1,0) [0|409.5] "m"  EOCM_F_FO
 SG_ FVisionWidthTrk11 : 61|6@0+ (0.25,0) [0|15.75] "m"  EOCM_F_FO
 SG_ FVisionMeasStatTrk11 : 63|2@0+ (1,0) [0|3] ""  EOCM_F_FO
 SG_ FwdVsnVertPosTrk11 : 53|6@0+ (0.25,-2) [-2|13.75] "deg"  EOCM_F_FO
 SG_ FVisionRelLaneTrk11 : 55|2@0+ (1,0) [0|3] ""  EOCM_F_FO
 SG_ FVisionAzRateTrk11 : 34|11@0- (0.125,0) [-128|127.875] "deg/sec"  EOCM_F_FO
 SG_ FVisionConfTrk11 : 36|2@0+ (1,0) [0|3] ""  EOCM_F_FO
 SG_ ObjDirTrk11 : 15|1@0+ (1,0) [0|1] ""  EOCM_F_FO
 SG_ FVisBurstIDTrk11 : 1|2@0+ (1,0) [0|3] ""  EOCM_F_FO
 SG_ FVisionObjectIDTrk11 : 7|6@0+ (1,0) [0|63] ""  EOCM_F_FO

BO_ 1100 F_Vision_Obj_Track_12_B: 8 VIS2_FO
 SG_ FwVsnCinCoutPotT12Rev : 5|2@0+ (1,0) [0|3] ""  EOCM_F_FO
 SG_ FwdVsnObjAgeTrk12 : 62|7@0+ (1,0) [0|127] ""  EOCM_F_FO
 SG_ FwdVsnLongVlctyTrk12 : 42|12@0- (0.0625,0) [-128|127.9375] "m/sec"  EOCM_F_FO
 SG_ FwdVsnLatOfstTrk12 : 36|10@0- (0.125,0) [-64|63.875] "m"  EOCM_F_FO
 SG_ FwdVsnBrkLtStatTrk12 : 38|2@0+ (1,0) [0|3] ""  EOCM_F_FO
 SG_ FwdVsnTrnSigStatTr12 : 25|3@0+ (1,0) [0|7] ""  EOCM_F_FO
 SG_ FwdVsnObjSclChgTrk12 : 15|16@0- (0.0002,0) [-6.5536|6.5534] "pix/sec"  EOCM_F_FO
 SG_ FrtVsnBrstIDAddInfo12 : 7|2@0+ (1,0) [0|3] ""  EOCM_F_FO

BO_ 1099 F_Vision_Obj_Track_11_B: 8 VIS2_FO
 SG_ FwVsnCinCoutPotT11Rev : 5|2@0+ (1,0) [0|3] ""  EOCM_F_FO
 SG_ FwdVsnObjAgeTrk11 : 62|7@0+ (1,0) [0|127] ""  EOCM_F_FO
 SG_ FwdVsnLongVlctyTrk11 : 42|12@0- (0.0625,0) [-128|127.9375] "m/sec"  EOCM_F_FO
 SG_ FwdVsnLatOfstTrk11 : 36|10@0- (0.125,0) [-64|63.875] "m"  EOCM_F_FO
 SG_ FwdVsnBrkLtStatTrk11 : 38|2@0+ (1,0) [0|3] ""  EOCM_F_FO
 SG_ FwdVsnTrnSigStatTr11 : 25|3@0+ (1,0) [0|7] ""  EOCM_F_FO
 SG_ FwdVsnObjSclChgTrk11 : 15|16@0- (0.0002,0) [-6.5536|6.5534] "pix/sec"  EOCM_F_FO
 SG_ FrtVsnBrstIDAddInfo11 : 7|2@0+ (1,0) [0|3] ""  EOCM_F_FO

BO_ 1098 F_Vision_Obj_Track_10_B: 8 VIS2_FO
 SG_ FwVsnCinCoutPotT10Rev : 5|2@0+ (1,0) [0|3] ""  EOCM_F_FO
 SG_ FwdVsnObjAgeTrk10 : 62|7@0+ (1,0) [0|127] ""  EOCM_F_FO
 SG_ FwdVsnLongVlctyTrk10 : 42|12@0- (0.0625,0) [-128|127.9375] "m/sec"  EOCM_F_FO
 SG_ FwdVsnLatOfstTrk10 : 36|10@0- (0.125,0) [-64|63.875] "m"  EOCM_F_FO
 SG_ FwdVsnBrkLtStatTrk10 : 38|2@0+ (1,0) [0|3] ""  EOCM_F_FO
 SG_ FwdVsnTrnSigStatTr10 : 25|3@0+ (1,0) [0|7] ""  EOCM_F_FO
 SG_ FwdVsnObjSclChgTrk10 : 15|16@0- (0.0002,0) [-6.5536|6.5534] "pix/sec"  EOCM_F_FO
 SG_ FrtVsnBrstIDAddInfo10 : 7|2@0+ (1,0) [0|3] ""  EOCM_F_FO

BO_ 1097 F_Vision_Obj_Track_9_B: 8 VIS2_FO
 SG_ FwVsnCinCoutPotT9Rev : 5|2@0+ (1,0) [0|3] ""  EOCM_F_FO
 SG_ FwdVsnObjAgeTrk9 : 62|7@0+ (1,0) [0|127] ""  EOCM_F_FO
 SG_ FwdVsnLongVlctyTrk9 : 42|12@0- (0.0625,0) [-128|127.9375] "m/sec"  EOCM_F_FO
 SG_ FwdVsnLatOfstTrk9 : 36|10@0- (0.125,0) [-64|63.875] "m"  EOCM_F_FO
 SG_ FwdVsnBrkLtStatTrk9 : 38|2@0+ (1,0) [0|3] ""  EOCM_F_FO
 SG_ FwdVsnTrnSigStatTr9 : 25|3@0+ (1,0) [0|7] ""  EOCM_F_FO
 SG_ FwdVsnObjSclChgTrk9 : 15|16@0- (0.0002,0) [-6.5536|6.5534] "pix/sec"  EOCM_F_FO
 SG_ FrtVsnBrstIDAddInfo9 : 7|2@0+ (1,0) [0|3] ""  EOCM_F_FO

BO_ 1096 F_Vision_Obj_Track_8_B: 8 VIS2_FO
 SG_ FwVsnCinCoutPotT8Rev : 5|2@0+ (1,0) [0|3] ""  EOCM_F_FO
 SG_ FwdVsnObjAgeTrk8 : 62|7@0+ (1,0) [0|127] ""  EOCM_F_FO
 SG_ FwdVsnLongVlctyTrk8 : 42|12@0- (0.0625,0) [-128|127.9375] "m/sec"  EOCM_F_FO
 SG_ FwdVsnLatOfstTrk8 : 36|10@0- (0.125,0) [-64|63.875] "m"  EOCM_F_FO
 SG_ FwdVsnBrkLtStatTrk8 : 38|2@0+ (1,0) [0|3] ""  EOCM_F_FO
 SG_ FwdVsnTrnSigStatTr8 : 25|3@0+ (1,0) [0|7] ""  EOCM_F_FO
 SG_ FwdVsnObjSclChgTrk8 : 15|16@0- (0.0002,0) [-6.5536|6.5534] "pix/sec"  EOCM_F_FO
 SG_ FrtVsnBrstIDAddInfo8 : 7|2@0+ (1,0) [0|3] ""  EOCM_F_FO

BO_ 1095 F_Vision_Obj_Track_7_B: 8 VIS2_FO
 SG_ FwVsnCinCoutPotT7Rev : 5|2@0+ (1,0) [0|3] ""  EOCM_F_FO
 SG_ FwdVsnObjAgeTrk7 : 62|7@0+ (1,0) [0|127] ""  EOCM_F_FO
 SG_ FwdVsnLongVlctyTrk7 : 42|12@0- (0.0625,0) [-128|127.9375] "m/sec"  EOCM_F_FO
 SG_ FwdVsnLatOfstTrk7 : 36|10@0- (0.125,0) [-64|63.875] "m"  EOCM_F_FO
 SG_ FwdVsnBrkLtStatTrk7 : 38|2@0+ (1,0) [0|3] ""  EOCM_F_FO
 SG_ FwdVsnTrnSigStatTr7 : 25|3@0+ (1,0) [0|7] ""  EOCM_F_FO
 SG_ FwdVsnObjSclChgTrk7 : 15|16@0- (0.0002,0) [-6.5536|6.5534] "pix/sec"  EOCM_F_FO
 SG_ FrtVsnBrstIDAddInfo7 : 7|2@0+ (1,0) [0|3] ""  EOCM_F_FO

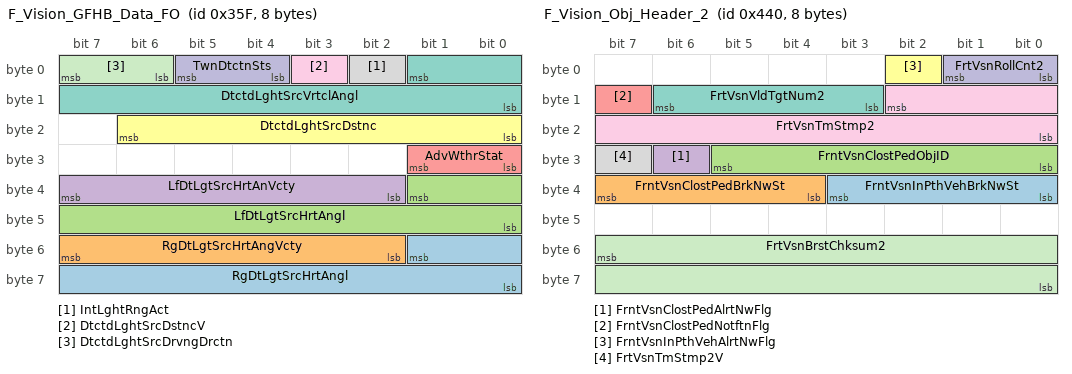
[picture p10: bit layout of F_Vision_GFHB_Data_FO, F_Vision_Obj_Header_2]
BO_ 863 F_Vision_GFHB_Data_FO: 8 VIS2_FO
 SG_ RgDtLgtSrcHrtAngl : 49|10@0- (0.04,0) [-20.48|20.44] "deg"  EOCM_F_FO
 SG_ RgDtLgtSrcHrtAngVcty : 55|6@0- (1,0) [-32|31] "deg/sec"  EOCM_F_FO
 SG_ LfDtLgtSrcHrtAngl : 33|10@0- (0.04,0) [-20.48|20.44] "deg"  EOCM_F_FO
 SG_ LfDtLgtSrcHrtAnVcty : 39|6@0- (1,0) [-32|31] "deg/sec"  EOCM_F_FO
 SG_ AdvWthrStat : 25|2@0+ (1,0) [0|3] ""  EOCM_F_FO
 SG_ DtctdLghtSrcDstnc : 22|7@0+ (10,0) [0|1270] "m"  EOCM_F_FO
 SG_ DtctdLghtSrcVrtclAngl : 1|10@0- (0.04,0) [-20.48|20.44] "deg"  EOCM_F_FO
 SG_ IntLghtRngAct : 2|1@0+ (1,0) [0|1] ""  EOCM_F_FO
 SG_ DtctdLghtSrcDstncV : 3|1@0+ (1,0) [0|1] ""  EOCM_F_FO
 SG_ TwnDtctnSts : 5|2@0+ (1,0) [0|3] ""  EOCM_F_FO
 SG_ DtctdLghtSrcDrvngDrctn : 7|2@0+ (1,0) [0|3] ""  EOCM_F_FO

BO_ 862 LGT_ControlHighBeamGlare_FO: 2 VIS2_FO
 SG_ FwdCamSysOpStat : 10|3@0+ (1,0) [0|7] ""  EOCM_F_FO
 SG_ EnvIllum : 2|3@0+ (1,0) [0|7] ""  EOCM_F_FO
 SG_ RdTyp : 5|3@0+ (1,0) [0|7] ""  EOCM_F_FO
 SG_ AutoHgBmSts : 7|2@0+ (1,0) [0|3] ""  EOCM_F_FO

BO_ 1068 F_Vision_Obj_Track_6_B: 8 VIS2_FO
 SG_ FwVsnCinCoutPotT6Rev : 5|2@0+ (1,0) [0|3] ""  EOCM_F_FO
 SG_ FwdVsnObjAgeTrk6 : 62|7@0+ (1,0) [0|127] ""  EOCM_F_FO
 SG_ FwdVsnLongVlctyTrk6 : 42|12@0- (0.0625,0) [-128|127.9375] "m/sec"  EOCM_F_FO
 SG_ FwdVsnLatOfstTrk6 : 36|10@0- (0.125,0) [-64|63.875] "m"  EOCM_F_FO
 SG_ FwdVsnBrkLtStatTrk6 : 38|2@0+ (1,0) [0|3] ""  EOCM_F_FO
 SG_ FwdVsnTrnSigStatTr6 : 25|3@0+ (1,0) [0|7] ""  EOCM_F_FO
 SG_ FwdVsnObjSclChgTrk6 : 15|16@0- (0.0002,0) [-6.5536|6.5534] "pix/sec"  EOCM_F_FO
 SG_ FrtVsnBrstIDAddInfo6 : 7|2@0+ (1,0) [0|3] ""  EOCM_F_FO

BO_ 1067 F_Vision_Obj_Track_5_B: 8 VIS2_FO
 SG_ FwVsnCinCoutPotT5Rev : 5|2@0+ (1,0) [0|3] ""  EOCM_F_FO
 SG_ FwdVsnObjAgeTrk5 : 62|7@0+ (1,0) [0|127] ""  EOCM_F_FO
 SG_ FwdVsnLongVlctyTrk5 : 42|12@0- (0.0625,0) [-128|127.9375] "m/sec"  EOCM_F_FO
 SG_ FwdVsnLatOfstTrk5 : 36|10@0- (0.125,0) [-64|63.875] "m"  EOCM_F_FO
 SG_ FwdVsnBrkLtStatTrk5 : 38|2@0+ (1,0) [0|3] ""  EOCM_F_FO
 SG_ FwdVsnTrnSigStatTr5 : 25|3@0+ (1,0) [0|7] ""  EOCM_F_FO
 SG_ FwdVsnObjSclChgTrk5 : 15|16@0- (0.0002,0) [-6.5536|6.5534] "pix/sec"  EOCM_F_FO
 SG_ FrtVsnBrstIDAddInfo5 : 7|2@0+ (1,0) [0|3] ""  EOCM_F_FO

BO_ 1066 F_Vision_Obj_Track_4_B: 8 VIS2_FO
 SG_ FwVsnCinCoutPotT4Rev : 5|2@0+ (1,0) [0|3] ""  EOCM_F_FO
 SG_ FwdVsnObjAgeTrk4 : 62|7@0+ (1,0) [0|127] ""  EOCM_F_FO
 SG_ FwdVsnLongVlctyTrk4 : 42|12@0- (0.0625,0) [-128|127.9375] "m/sec"  EOCM_F_FO
 SG_ FwdVsnLatOfstTrk4 : 36|10@0- (0.125,0) [-64|63.875] "m"  EOCM_F_FO
 SG_ FwdVsnBrkLtStatTrk4 : 38|2@0+ (1,0) [0|3] ""  EOCM_F_FO
 SG_ FwdVsnTrnSigStatTr4 : 25|3@0+ (1,0) [0|7] ""  EOCM_F_FO
 SG_ FwdVsnObjSclChgTrk4 : 15|16@0- (0.0002,0) [-6.5536|6.5534] "pix/sec"  EOCM_F_FO
 SG_ FrtVsnBrstIDAddInfo4 : 7|2@0+ (1,0) [0|3] ""  EOCM_F_FO

BO_ 1065 F_Vision_Obj_Track_3_B: 8 VIS2_FO
 SG_ FwVsnCinCoutPotT3Rev : 5|2@0+ (1,0) [0|3] ""  EOCM_F_FO
 SG_ FwdVsnObjAgeTrk3 : 62|7@0+ (1,0) [0|127] ""  EOCM_F_FO
 SG_ FwdVsnLongVlctyTrk3 : 42|12@0- (0.0625,0) [-128|127.9375] "m/sec"  EOCM_F_FO
 SG_ FwdVsnLatOfstTrk3 : 36|10@0- (0.125,0) [-64|63.875] "m"  EOCM_F_FO
 SG_ FwdVsnBrkLtStatTrk3 : 38|2@0+ (1,0) [0|3] ""  EOCM_F_FO
 SG_ FwdVsnTrnSigStatTr3 : 25|3@0+ (1,0) [0|7] ""  EOCM_F_FO
 SG_ FwdVsnObjSclChgTrk3 : 15|16@0- (0.0002,0) [-6.5536|6.5534] "pix/sec"  EOCM_F_FO
 SG_ FrtVsnBrstIDAddInfo3 : 7|2@0+ (1,0) [0|3] ""  EOCM_F_FO

BO_ 1064 F_Vision_Obj_Track_2_B: 8 VIS2_FO
 SG_ FwVsnCinCoutPotT2Rev : 5|2@0+ (1,0) [0|3] ""  EOCM_F_FO
 SG_ FwdVsnObjAgeTrk2 : 62|7@0+ (1,0) [0|127] ""  EOCM_F_FO
 SG_ FwdVsnLongVlctyTrk2 : 42|12@0- (0.0625,0) [-128|127.9375] "m/sec"  EOCM_F_FO
 SG_ FwdVsnLatOfstTrk2 : 36|10@0- (0.125,0) [-64|63.875] "m"  EOCM_F_FO
 SG_ FwdVsnBrkLtStatTrk2 : 38|2@0+ (1,0) [0|3] ""  EOCM_F_FO
 SG_ FwdVsnTrnSigStatTr2 : 25|3@0+ (1,0) [0|7] ""  EOCM_F_FO
 SG_ FwdVsnObjSclChgTrk2 : 15|16@0- (0.0002,0) [-6.5536|6.5534] "pix/sec"  EOCM_F_FO
 SG_ FrtVsnBrstIDAddInfo2 : 7|2@0+ (1,0) [0|3] ""  EOCM_F_FO

BO_ 1063 F_Vision_Obj_Track_1_B: 8 VIS2_FO
 SG_ FwVsnCinCoutPotT1Rev : 5|2@0+ (1,0) [0|3] ""  EOCM_F_FO
 SG_ FwdVsnObjSclChgTrk1 : 15|16@0- (0.0002,0) [-6.5536|6.5534] "pix/sec"  EOCM_F_FO
 SG_ FwdVsnObjAgeTrk1 : 62|7@0+ (1,0) [0|127] ""  EOCM_F_FO
 SG_ FwdVsnLongVlctyTrk1 : 42|12@0- (0.0625,0) [-128|127.9375] "m/sec"  EOCM_F_FO
 SG_ FwdVsnLatOfstTrk1 : 36|10@0- (0.125,0) [-64|63.875] "m"  EOCM_F_FO
 SG_ FwdVsnBrkLtStatTrk1 : 38|2@0+ (1,0) [0|3] ""  EOCM_F_FO
 SG_ FwdVsnTrnSigStatTr1 : 25|3@0+ (1,0) [0|7] ""  EOCM_F_FO
 SG_ FrtVsnBrstIDAddInfo1 : 7|2@0+ (1,0) [0|3] ""  EOCM_F_FO

BO_ 1151 Long_Range_Radar_add_Info_5_FO: 8 LRR_FO
 SG_ FrtRdrRdEdgLtLatRdEdgDst : 63|8@0- (0.1,0) [-12.8|12.7] "m/m"  EOCM_F_FO
 SG_ FrtRdrRdEdgLtCrvtPrvDst : 5|4@0+ (10,0) [0|150] ""  EOCM_F_FO
 SG_ FrtRdrRdEdgLtTanHdgAng : 15|8@0- (0.002,0) [-0.256|0.254] "m/m"  EOCM_F_FO
 SG_ FrtRdrRdEdgLtCrvtV : 48|1@0+ (1,0) [0|1] ""  EOCM_F_FO
 SG_ FrtRdrRdEdgLtCrvtGradV : 0|1@0+ (1,0) [0|1] ""  EOCM_F_FO
 SG_ FrtRdrRdEdgLtCrvtGrad : 39|16@0- (5.96E-008,0) [-0.0019529728|0.0019529132] "1/(m*sec)"  EOCM_F_FO
 SG_ FrtRdrRdEdgLtCrvtConf : 55|7@0+ (0.7874016,0) [0|100.0000032] "%"  EOCM_F_FO
 SG_ FrtRdrRdEdgLtCrvt : 23|16@0- (9.53E-007,0) [-0.031227904|0.031226951] "1/m"  EOCM_F_FO
 SG_ FrtRdrRdEdgLtTanHdgAngV : 1|1@0+ (1,0) [0|1] ""  EOCM_F_FO
 SG_ FLRRAddInfo5BurstID : 7|2@0+ (1,0) [0|3] ""  EOCM_F_FO

BO_ 1150 Long_Range_Radar_add_Info_4_FO: 8 LRR_FO
 SG_ FrtRdrRdEdgRtLatRdEdgDst : 63|8@0- (0.1,0) [-12.8|12.7] "m/m"  EOCM_F_FO
 SG_ FrtRdrRdEdgRtCrvtPrvDst : 5|4@0+ (10,0) [0|150] ""  EOCM_F_FO
 SG_ FrtRdrRdEdgRtTanHdgAngV : 1|1@0+ (1,0) [0|1] ""  EOCM_F_FO
 SG_ FrtRdrRdEdgRtTanHdgAng : 15|8@0- (0.002,0) [-0.256|0.254] "m/m"  EOCM_F_FO
 SG_ FrtRdrRdEdgRtCrvtV : 48|1@0+ (1,0) [0|1] ""  EOCM_F_FO
 SG_ FrtRdrRdEdgRtCrvtGradV : 0|1@0+ (1,0) [0|1] ""  EOCM_F_FO
 SG_ FrtRdrRdEdgRtCrvtGrad : 39|16@0- (5.96E-008,0) [-0.0019529728|0.0019529132] "1/(m*sec)"  EOCM_F_FO
 SG_ FrtRdrRdEdgRtCrvtConf : 55|7@0+ (0.7874016,0) [0|100.0000032] "%"  EOCM_F_FO
 SG_ FrtRdrRdEdgRtCrvt : 23|16@0- (9.53E-007,0) [-0.031227904|0.031226951] "1/m"  EOCM_F_FO
 SG_ FLRRAddInfo4BurstID : 7|2@0+ (1,0) [0|3] ""  EOCM_F_FO

BO_ 1088 F_Vision_Obj_Header_2: 8 VIS2_FO
 SG_ FrntVsnInPthVehBrkNwSt : 35|4@0+ (1,0) [0|15] ""  EOCM_F_FO
 SG_ FrntVsnClostPedBrkNwSt : 39|4@0+ (1,0) [0|15] ""  EOCM_F_FO
 SG_ FrntVsnClostPedObjID : 29|6@0+ (1,0) [0|63] ""  EOCM_F_FO
 SG_ FrntVsnClostPedAlrtNwFlg : 30|1@0+ (1,0) [0|1] ""  EOCM_F_FO
 SG_ FrntVsnClostPedNotftnFlg : 15|1@0+ (1,0) [0|1] ""  EOCM_F_FO
 SG_ FrntVsnInPthVehAlrtNwFlg : 2|1@0+ (1,0) [0|1] ""  EOCM_F_FO
 SG_ FrtVsnVldTgtNum2 : 14|4@0+ (1,0) [0|15] ""  EOCM_F_FO
 SG_ FrtVsnTmStmp2V : 31|1@0+ (1,0) [0|1] ""  EOCM_F_FO
 SG_ FrtVsnTmStmp2 : 10|11@0+ (1,0) [0|2047] ""  EOCM_F_FO
 SG_ FrtVsnRollCnt2 : 1|2@0+ (1,0) [0|3] ""  EOCM_F_FO
 SG_ FrtVsnBrstChksum2 : 55|16@0+ (1,0) [0|65535] ""  EOCM_F_FO

BO_ 854 F_Vision_Environment_7: 3 VIS2_FO
 SG_ FwdVsnCnstrctAreaDst : 13|4@0+ (10,0) [0|150] "m"  EOCM2A_IMX6_FO,EOCM2A_K2_FO,EOCM2A_K1_FO,EOCM2B_IMX6_FO,EOCM2B_K2_FO,EOCM2B_K1_FO,EOCM_F_FO
 SG_ FwdVsnCnstrctZnDet : 15|2@0+ (1,0) [0|3] ""  EOCM2A_IMX6_FO,EOCM2A_K2_FO,EOCM2A_K1_FO,EOCM2B_IMX6_FO,EOCM2B_K2_FO,EOCM2B_K1_FO,EOCM_F_FO
 SG_ FwdVsnEgoVehLnPos : 17|2@0+ (1,0) [0|3] ""  EOCM2A_IMX6_FO,EOCM2A_K2_FO,EOCM2A_K1_FO,EOCM2B_IMX6_FO,EOCM2B_K2_FO,EOCM2B_K1_FO,EOCM_F_FO
 SG_ FwdVsnRdTypDet : 9|2@0+ (1,0) [0|3] ""  EOCM2A_IMX6_FO,EOCM2A_K2_FO,EOCM2A_K1_FO,EOCM2B_IMX6_FO,EOCM2B_K2_FO,EOCM2B_K1_FO,EOCM_F_FO
 SG_ FwdVsnTunnlDetd : 23|2@0+ (1,0) [0|3] ""  EOCM2A_IMX6_FO,EOCM2A_K2_FO,EOCM2A_K1_FO,EOCM2B_IMX6_FO,EOCM2B_K2_FO,EOCM2B_K1_FO,EOCM_F_FO
 SG_ FwdVsnTunnlDst : 21|4@0+ (10,0) [0|150] "m"  EOCM2A_IMX6_FO,EOCM2A_K2_FO,EOCM2A_K1_FO,EOCM2B_IMX6_FO,EOCM2B_K2_FO,EOCM2B_K1_FO,EOCM_F_FO
 SG_ LnSnsBrstID5 : 1|2@0+ (1,0) [0|3] ""  EOCM2A_IMX6_FO,EOCM2A_K2_FO,EOCM2A_K1_FO,EOCM2B_IMX6_FO,EOCM2B_K2_FO,EOCM2B_K1_FO,EOCM_F_FO

BO_ 853 F_Vision_Environment_6: 8 VIS2_FO
 SG_ LnMrkg4LnSnsLnHdngTngtV : 7|1@0+ (1,0) [0|1] ""  EOCM2A_IMX6_FO,EOCM2A_K2_FO,EOCM2A_K1_FO,EOCM2B_IMX6_FO,EOCM2B_K2_FO,EOCM2B_K1_FO,EOCM_F_FO
 SG_ LnMrkg4LnSnsLnHdngTngt : 23|8@0- (0.002,0) [-0.256|0.254] "m/m"  EOCM2A_IMX6_FO,EOCM2A_K2_FO,EOCM2A_K1_FO,EOCM2B_IMX6_FO,EOCM2B_K2_FO,EOCM2B_K1_FO,EOCM_F_FO
 SG_ LnMrkg4LnSnsLnDstV : 56|1@0+ (1,0) [0|1] ""  EOCM2A_IMX6_FO,EOCM2A_K2_FO,EOCM2A_K1_FO,EOCM2B_IMX6_FO,EOCM2B_K2_FO,EOCM2B_K1_FO,EOCM_F_FO
 SG_ LnMrkg4LnSnsLnDst : 15|8@0- (0.1,0) [-12.8|12.7] "m"  EOCM2A_IMX6_FO,EOCM2A_K2_FO,EOCM2A_K1_FO,EOCM2B_IMX6_FO,EOCM2B_K2_FO,EOCM2B_K1_FO,EOCM_F_FO
 SG_ LnMrkg4LnSnsLnCrvtV : 6|1@0+ (1,0) [0|1] ""  EOCM2A_IMX6_FO,EOCM2A_K2_FO,EOCM2A_K1_FO,EOCM2B_IMX6_FO,EOCM2B_K2_FO,EOCM2B_K1_FO,EOCM_F_FO
 SG_ LnMrkg4LnSnsLnCrvtGradV : 5|1@0+ (1,0) [0|1] ""  EOCM2A_IMX6_FO,EOCM2A_K2_FO,EOCM2A_K1_FO,EOCM2B_IMX6_FO,EOCM2B_K2_FO,EOCM2B_K1_FO,EOCM_F_FO
 SG_ LnMrkg4LnSnsLnCrvtGrad : 47|16@0- (5.96E-008,0) [-0.0019529728|0.0019529132] "1/(m*sec)"  EOCM2A_IMX6_FO,EOCM2A_K2_FO,EOCM2A_K1_FO,EOCM2B_IMX6_FO,EOCM2B_K2_FO,EOCM2B_K1_FO,EOCM_F_FO
 SG_ LnMrkg4LnSnsLnCrvt : 31|16@0- (9.53E-007,0) [-0.031227904|0.031226951] "1/m"  EOCM2A_IMX6_FO,EOCM2A_K2_FO,EOCM2A_K1_FO,EOCM2B_IMX6_FO,EOCM2B_K2_FO,EOCM2B_K1_FO,EOCM_F_FO
 SG_ LnMrkg4LnQltyConfLvl : 63|7@0+ (0.7874016,0) [0|100.0000032] "%"  EOCM2A_IMX6_FO,EOCM2A_K2_FO,EOCM2A_K1_FO,EOCM2B_IMX6_FO,EOCM2B_K2_FO,EOCM2B_K1_FO,EOCM_F_FO
 SG_ LnMrkg4LnMrkrTyp : 4|3@0+ (1,0) [0|7] ""  EOCM2A_IMX6_FO,EOCM2A_K2_FO,EOCM2A_K1_FO,EOCM2B_IMX6_FO,EOCM2B_K2_FO,EOCM2B_K1_FO,EOCM_F_FO
 SG_ LnSnsBrstID4 : 1|2@0+ (1,0) [0|3] ""  EOCM2A_IMX6_FO,EOCM2A_K2_FO,EOCM2A_K1_FO,EOCM2B_IMX6_FO,EOCM2B_K2_FO,EOCM2B_K1_FO,EOCM_F_FO

BO_ 852 F_Vision_Environment_5: 8 VIS2_FO
 SG_ LnMrkg3LnSnsLnHdngTngtV : 7|1@0+ (1,0) [0|1] ""  EOCM2A_IMX6_FO,EOCM2A_K2_FO,EOCM2A_K1_FO,EOCM2B_IMX6_FO,EOCM2B_K2_FO,EOCM2B_K1_FO,EOCM_F_FO
 SG_ LnMrkg3LnSnsLnHdngTngt : 23|8@0- (0.002,0) [-0.256|0.254] "m/m"  EOCM2A_IMX6_FO,EOCM2A_K2_FO,EOCM2A_K1_FO,EOCM2B_IMX6_FO,EOCM2B_K2_FO,EOCM2B_K1_FO,EOCM_F_FO
 SG_ LnMrkg3LnSnsLnDstV : 56|1@0+ (1,0) [0|1] ""  EOCM2A_IMX6_FO,EOCM2A_K2_FO,EOCM2A_K1_FO,EOCM2B_IMX6_FO,EOCM2B_K2_FO,EOCM2B_K1_FO,EOCM_F_FO
 SG_ LnMrkg3LnSnsLnDst : 15|8@0- (0.1,0) [-12.8|12.7] "m"  EOCM2A_IMX6_FO,EOCM2A_K2_FO,EOCM2A_K1_FO,EOCM2B_IMX6_FO,EOCM2B_K2_FO,EOCM2B_K1_FO,EOCM_F_FO
 SG_ LnMrkg3LnSnsLnCrvtV : 6|1@0+ (1,0) [0|1] ""  EOCM2A_IMX6_FO,EOCM2A_K2_FO,EOCM2A_K1_FO,EOCM2B_IMX6_FO,EOCM2B_K2_FO,EOCM2B_K1_FO,EOCM_F_FO
 SG_ LnMrkg3LnSnsLnCrvtGradV : 5|1@0+ (1,0) [0|1] ""  EOCM2A_IMX6_FO,EOCM2A_K2_FO,EOCM2A_K1_FO,EOCM2B_IMX6_FO,EOCM2B_K2_FO,EOCM2B_K1_FO,EOCM_F_FO
 SG_ LnMrkg3LnSnsLnCrvtGrad : 47|16@0- (5.96E-008,0) [-0.0019529728|0.0019529132] "1/(m*sec)"  EOCM2A_IMX6_FO,EOCM2A_K2_FO,EOCM2A_K1_FO,EOCM2B_IMX6_FO,EOCM2B_K2_FO,EOCM2B_K1_FO,EOCM_F_FO
 SG_ LnMrkg3LnSnsLnCrvt : 31|16@0- (9.53E-007,0) [-0.031227904|0.031226951] "1/m"  EOCM2A_IMX6_FO,EOCM2A_K2_FO,EOCM2A_K1_FO,EOCM2B_IMX6_FO,EOCM2B_K2_FO,EOCM2B_K1_FO,EOCM_F_FO
 SG_ LnMrkg3LnQltyConfLvl : 63|7@0+ (0.7874016,0) [0|100.0000032] "%"  EOCM2A_IMX6_FO,EOCM2A_K2_FO,EOCM2A_K1_FO,EOCM2B_IMX6_FO,EOCM2B_K2_FO,EOCM2B_K1_FO,EOCM_F_FO
 SG_ LnMrkg3LnMrkrTyp : 4|3@0+ (1,0) [0|7] ""  EOCM2A_IMX6_FO,EOCM2A_K2_FO,EOCM2A_K1_FO,EOCM2B_IMX6_FO,EOCM2B_K2_FO,EOCM2B_K1_FO,EOCM_F_FO
 SG_ LnSnsBrstID3 : 1|2@0+ (1,0) [0|3] ""  EOCM2A_IMX6_FO,EOCM2A_K2_FO,EOCM2A_K1_FO,EOCM2B_IMX6_FO,EOCM2B_K2_FO,EOCM2B_K1_FO,EOCM_F_FO

BO_ 602 USDT_Req_to_RRSRR: 8 TestTool_FO
 SG_ DgnInf : 7|64@0+ (1,0) [0|1.84467440737096E+019] ""  RRSRR_FO

BO_ 1626 USDT_Resp_From_RRSRR: 8 RRSRR_FO
 SG_ DgnInf_OBJ65A : 7|64@0+ (1,0) [0|1.84467440737096E+019] ""  TestTool_FO

BO_ 1370 UUDT_Resp_From_RRSRR: 8 RRSRR_FO
 SG_ DgnInf_OBJ55A : 7|64@0+ (1,0) [0|1.84467440737096E+019] ""  TestTool_FO

BO_ 1536 RR_SRR_Trace_data: 8 RRSRR_FO
 SG_ RRSRRYear : 7|8@0+ (1,0) [0|0] ""  EOCM_F_FO
 SG_ RRSRRSerialNmbr : 39|32@0+ (1,0) [0|0] ""  EOCM_F_FO
 SG_ RRSRRJulianDate : 15|24@0+ (1,0) [0|0] ""  EOCM_F_FO

BO_ 1210 RR_SRR_Object_Track10: 8 RRSRR_FO
 SG_ RRSrrTrkRawAzimuth10 : 61|6@0- (1,0) [-32|31] "deg"  EOCM_F_FO
 SG_ RRSrrTrkRRate10 : 18|11@0- (0.125,0) [-128|127.875] "m/s"  EOCM_F_FO
 SG_ RRSrrTrkRange10 : 2|11@0+ (0.02,0) [0|40.94] "m"  EOCM_F_FO
 SG_ RRSrrTrkObsRange10 : 53|6@0- (0.02,0) [-0.64|0.62] "m"  EOCM_F_FO
 SG_ RRSrrTrkObjID10 : 39|5@0+ (1,0) [0|31] ""  EOCM_F_FO
 SG_ RRSrrTrkObjElevation10 : 20|2@0+ (1,0) [0|3] ""  EOCM_F_FO
 SG_ RRSrrTrkMeasStatus10 : 55|2@0+ (1,0) [0|3] ""  EOCM_F_FO
 SG_ RRSrrTrkDynamProp10 : 23|3@0+ (1,0) [0|7] ""  EOCM_F_FO
 SG_ RRSrrTrkAzimuth10 : 34|11@0- (0.125,0) [-128|127.875] "deg"  EOCM_F_FO
 SG_ RRSrrBurstID10 : 63|2@0+ (1,0) [0|3] ""  EOCM_F_FO

BO_ 1209 RR_SRR_Object_Track9: 8 RRSRR_FO
 SG_ RRSrrTrkRawAzimuth9 : 61|6@0- (1,0) [-32|31] "deg"  EOCM_F_FO
 SG_ RRSrrTrkRRate9 : 18|11@0- (0.125,0) [-128|127.875] "m/s"  EOCM_F_FO
 SG_ RRSrrTrkRange9 : 2|11@0+ (0.02,0) [0|40.94] "m"  EOCM_F_FO
 SG_ RRSrrTrkObsRange9 : 53|6@0- (0.02,0) [-0.64|0.62] "m"  EOCM_F_FO
 SG_ RRSrrTrkObjID9 : 39|5@0+ (1,0) [0|31] ""  EOCM_F_FO
 SG_ RRSrrTrkObjElevation9 : 20|2@0+ (1,0) [0|3] ""  EOCM_F_FO
 SG_ RRSrrTrkMeasStatus9 : 55|2@0+ (1,0) [0|3] ""  EOCM_F_FO
 SG_ RRSrrTrkDynamProp9 : 23|3@0+ (1,0) [0|7] ""  EOCM_F_FO
 SG_ RRSrrTrkAzimuth9 : 34|11@0- (0.125,0) [-128|127.875] "deg"  EOCM_F_FO
 SG_ RRSrrBurstID9 : 63|2@0+ (1,0) [0|3] ""  EOCM_F_FO

BO_ 1208 RR_SRR_Object_Track8: 8 RRSRR_FO
 SG_ RRSrrTrkRawAzimuth8 : 61|6@0- (1,0) [-32|31] "deg"  EOCM_F_FO
 SG_ RRSrrTrkRRate8 : 18|11@0- (0.125,0) [-128|127.875] "m/s"  EOCM_F_FO
 SG_ RRSrrTrkRange8 : 2|11@0+ (0.02,0) [0|40.94] "m"  EOCM_F_FO
 SG_ RRSrrTrkObsRange8 : 53|6@0- (0.02,0) [-0.64|0.62] "m"  EOCM_F_FO
 SG_ RRSrrTrkObjID8 : 39|5@0+ (1,0) [0|31] ""  EOCM_F_FO
 SG_ RRSrrTrkObjElevation8 : 20|2@0+ (1,0) [0|3] ""  EOCM_F_FO
 SG_ RRSrrTrkMeasStatus8 : 55|2@0+ (1,0) [0|3] ""  EOCM_F_FO
 SG_ RRSrrTrkDynamProp8 : 23|3@0+ (1,0) [0|7] ""  EOCM_F_FO
 SG_ RRSrrTrkAzimuth8 : 34|11@0- (0.125,0) [-128|127.875] "deg"  EOCM_F_FO
 SG_ RRSrrBurstID8 : 63|2@0+ (1,0) [0|3] ""  EOCM_F_FO

BO_ 1207 RR_SRR_Object_Track7: 8 RRSRR_FO
 SG_ RRSrrTrkRawAzimuth7 : 61|6@0- (1,0) [-32|31] "deg"  EOCM_F_FO
 SG_ RRSrrTrkRRate7 : 18|11@0- (0.125,0) [-128|127.875] "m/s"  EOCM_F_FO
 SG_ RRSrrTrkRange7 : 2|11@0+ (0.02,0) [0|40.94] "m"  EOCM_F_FO
 SG_ RRSrrTrkObsRange7 : 53|6@0- (0.02,0) [-0.64|0.62] "m"  EOCM_F_FO
 SG_ RRSrrTrkObjID7 : 39|5@0+ (1,0) [0|31] ""  EOCM_F_FO
 SG_ RRSrrTrkObjElevation7 : 20|2@0+ (1,0) [0|3] ""  EOCM_F_FO
 SG_ RRSrrTrkMeasStatus7 : 55|2@0+ (1,0) [0|3] ""  EOCM_F_FO
 SG_ RRSrrTrkDynamProp7 : 23|3@0+ (1,0) [0|7] ""  EOCM_F_FO
 SG_ RRSrrTrkAzimuth7 : 34|11@0- (0.125,0) [-128|127.875] "deg"  EOCM_F_FO
 SG_ RRSrrBurstID7 : 63|2@0+ (1,0) [0|3] ""  EOCM_F_FO

BO_ 1206 RR_SRR_Object_Track6: 8 RRSRR_FO
 SG_ RRSrrTrkRawAzimuth6 : 61|6@0- (1,0) [-32|31] "deg"  EOCM_F_FO
 SG_ RRSrrTrkRRate6 : 18|11@0- (0.125,0) [-128|127.875] "m/s"  EOCM_F_FO
 SG_ RRSrrTrkRange6 : 2|11@0+ (0.02,0) [0|40.94] "m"  EOCM_F_FO
 SG_ RRSrrTrkObsRange6 : 53|6@0- (0.02,0) [-0.64|0.62] "m"  EOCM_F_FO
 SG_ RRSrrTrkObjID6 : 39|5@0+ (1,0) [0|31] ""  EOCM_F_FO
 SG_ RRSrrTrkObjElevation6 : 20|2@0+ (1,0) [0|3] ""  EOCM_F_FO
 SG_ RRSrrTrkMeasStatus6 : 55|2@0+ (1,0) [0|3] ""  EOCM_F_FO
 SG_ RRSrrTrkDynamProp6 : 23|3@0+ (1,0) [0|7] ""  EOCM_F_FO
 SG_ RRSrrTrkAzimuth6 : 34|11@0- (0.125,0) [-128|127.875] "deg"  EOCM_F_FO
 SG_ RRSrrBurstID6 : 63|2@0+ (1,0) [0|3] ""  EOCM_F_FO

BO_ 1205 RR_SRR_Object_Track5: 8 RRSRR_FO
 SG_ RRSrrTrkRawAzimuth5 : 61|6@0- (1,0) [-32|31] "deg"  EOCM_F_FO
 SG_ RRSrrTrkRRate5 : 18|11@0- (0.125,0) [-128|127.875] "m/s"  EOCM_F_FO
 SG_ RRSrrTrkRange5 : 2|11@0+ (0.02,0) [0|40.94] "m"  EOCM_F_FO
 SG_ RRSrrTrkObsRange5 : 53|6@0- (0.02,0) [-0.64|0.62] "m"  EOCM_F_FO
 SG_ RRSrrTrkObjID5 : 39|5@0+ (1,0) [0|31] ""  EOCM_F_FO
 SG_ RRSrrTrkObjElevation5 : 20|2@0+ (1,0) [0|3] ""  EOCM_F_FO
 SG_ RRSrrTrkMeasStatus5 : 55|2@0+ (1,0) [0|3] ""  EOCM_F_FO
 SG_ RRSrrTrkDynamProp5 : 23|3@0+ (1,0) [0|7] ""  EOCM_F_FO
 SG_ RRSrrTrkAzimuth5 : 34|11@0- (0.125,0) [-128|127.875] "deg"  EOCM_F_FO
 SG_ RRSrrBurstID5 : 63|2@0+ (1,0) [0|3] ""  EOCM_F_FO

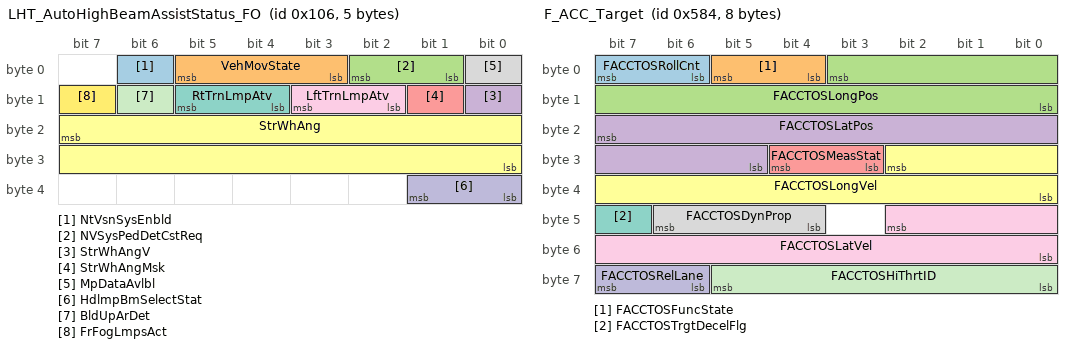
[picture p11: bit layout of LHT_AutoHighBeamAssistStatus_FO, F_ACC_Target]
BO_ 262 LHT_AutoHighBeamAssistStatus_FO: 5 EOCM_F_FO
 SG_ NtVsnSysEnbld : 6|1@0+ (1,0) [0|1] ""  EOCM2B_IMX6_FO,EOCM2B_K2_FO,EOCM2B_K1_FO,NVS_FO
 SG_ VehMovState : 5|3@0+ (1,0) [0|7] ""  EOCM2B_IMX6_FO,EOCM2B_K2_FO,EOCM2B_K1_FO,NVS_FO
 SG_ NVSysPedDetCstReq : 2|2@0+ (1,0) [0|3] ""  EOCM2B_IMX6_FO,EOCM2B_K2_FO,EOCM2B_K1_FO,NVS_FO
 SG_ StrWhAngV : 8|1@0+ (1,0) [0|1] ""  EOCM2B_IMX6_FO,EOCM2B_K2_FO,EOCM2B_K1_FO,NVS_FO,VIS_FO
 SG_ StrWhAngMsk : 9|1@0+ (1,0) [0|1] ""  EOCM2B_IMX6_FO,EOCM2B_K2_FO,EOCM2B_K1_FO,VIS_FO
 SG_ StrWhAng : 23|16@0- (0.0625,0) [-2048|2047.9375] "deg"  EOCM2B_IMX6_FO,EOCM2B_K2_FO,EOCM2B_K1_FO,NVS_FO,VIS_FO
 SG_ RtTrnLmpAtv : 13|2@0+ (1,0) [0|3] ""  EOCM2B_IMX6_FO,EOCM2B_K2_FO,EOCM2B_K1_FO,VIS_FO
 SG_ MpDataAvlbl : 0|1@0+ (1,0) [0|1] ""  EOCM2B_IMX6_FO,EOCM2B_K2_FO,EOCM2B_K1_FO,VIS_FO
 SG_ LftTrnLmpAtv : 11|2@0+ (1,0) [0|3] ""  EOCM2B_IMX6_FO,EOCM2B_K2_FO,EOCM2B_K1_FO,VIS_FO
 SG_ HdlmpBmSelectStat : 33|2@0+ (1,0) [0|3] ""  EOCM2B_IMX6_FO,EOCM2B_K2_FO,EOCM2B_K1_FO,VIS_FO
 SG_ BldUpArDet : 14|1@0+ (1,0) [0|1] ""  EOCM2B_IMX6_FO,EOCM2B_K2_FO,EOCM2B_K1_FO,VIS_FO
 SG_ FrFogLmpsAct : 15|1@0+ (1,0) [0|1] ""  EOCM2B_IMX6_FO,EOCM2B_K2_FO,EOCM2B_K1_FO,NVS_FO,VIS_FO

BO_ 309 LHT_CameraObjConfirmation_FO: 1 VIS_FO
 SG_ HiBmRecmnd : 1|1@0+ (1,0) [0|1] ""  EOCM_F_FO
 SG_ CtLghtDet : 0|1@0+ (1,0) [0|1] ""  EOCM_F_FO

BO_ 2034 CCP_Data_Transmission_Object_FO: 8 VIS2_FO
 SG_ DgnInf : 7|64@0+ (1,0) [0|1.84467440737096E+019] ""  TestTool_FO

BO_ 2032 CCP_Command_Receive_Object_FO: 8 TestTool_FO
 SG_ DgnInf : 7|64@0+ (1,0) [0|1.84467440737096E+019] ""  VIS2_FO

BO_ 1362 F_Vis_Obj_Conf_CPS_1B: 8 EOCM_F_FO
 SG_ FObjConfCPSTrkObjectIDB : 7|6@0+ (1,0) [0|63] ""  VIS_FO
 SG_ CPSVisConfLonPos1 : 20|12@0- (0.125,0) [-256|255.875] "m"  VIS_FO
 SG_ CPSVisConfLatPos1 : 15|10@0- (0.125,0) [-64|63.875] "m"  VIS_FO
 SG_ CPSVisConfChecksum : 50|11@0+ (1,0) [0|2047] ""  VIS_FO
 SG_ FObjConfCPSTrkRangeRate : 45|11@0- (0.125,0) [-128|127.875] "m/s"  VIS_FO
 SG_ CPSConfTimeStamp : 24|11@0+ (1,0) [0|2047] "ms"  VIS_FO
 SG_ CPSConfTimeStampV : 21|1@0+ (1,0) [0|1] ""  VIS_FO
 SG_ FObjConfCPSRollingTrkCnt : 1|2@0+ (1,0) [0|3] ""  VIS_FO

BO_ 1413 TOS_ACC_IDS: 5 EOCM_F_FO
 SG_ TOS_ACC_IDSRollCnt : 7|2@0+ (1,0) [0|3] ""  Dummy_FO
 SG_ TOS_ACC_IDSFuncState : 5|2@0+ (1,0) [0|3] ""  Dummy_FO
 SG_ TOS_ACC_ID1 : 3|6@0+ (1,0) [0|63] ""  Dummy_FO
 SG_ TOS_ACC_ID2 : 13|6@0+ (1,0) [0|63] ""  Dummy_FO
 SG_ TOS_ACC_ID3 : 23|6@0+ (1,0) [0|63] ""  Dummy_FO
 SG_ TOS_ACC_ID4 : 17|6@0+ (1,0) [0|63] ""  Dummy_FO
 SG_ TOS_ACC_ID5 : 27|6@0+ (1,0) [0|63] ""  Dummy_FO
 SG_ TOS_ACC_ID6 : 37|6@0+ (1,0) [0|63] ""  Dummy_FO

BO_ 1412 F_ACC_Target: 8 EOCM_F_FO
 SG_ FACCTOSRollCnt : 7|2@0+ (1,0) [0|3] ""  Dummy_FO
 SG_ FACCTOSFuncState : 5|2@0+ (1,0) [0|3] ""  Dummy_FO
 SG_ FACCTOSLongPos : 3|12@0- (0.125,0) [-256|255.875] "m"  Dummy_FO
 SG_ FACCTOSLatPos : 23|11@0- (0.125,0) [-128|127.875] "m"  Dummy_FO
 SG_ FACCTOSMeasStat : 28|2@0+ (1,0) [0|3] ""  Dummy_FO
 SG_ FACCTOSLongVel : 26|11@0- (0.125,0) [-128|127.875] "m/s"  Dummy_FO
 SG_ FACCTOSTrgtDecelFlg : 47|1@0+ (1,0) [0|1] ""  Dummy_FO
 SG_ FACCTOSDynProp : 46|3@0+ (1,0) [0|7] ""  Dummy_FO
 SG_ FACCTOSLatVel : 42|11@0- (0.125,0) [-128|127.875] "m/s"  Dummy_FO
 SG_ FACCTOSRelLane : 63|2@0+ (1,0) [0|3] ""  Dummy_FO
 SG_ FACCTOSHiThrtID : 61|6@0+ (1,0) [0|63] ""  Dummy_FO

BO_ 1409 F_CPS_TOS_B: 8 EOCM_F_FO
 SG_ CPSTOSObjType : 7|3@0+ (1,0) [0|7] ""  Dummy_FO
 SG_ CPSTOSHiThrtPriNo : 60|5@0+ (1,0) [0|31] ""  Dummy_FO
 SG_ CPSTOSRelLongAcc : 53|9@0- (0.125,0) [-32|31.875] "m/s^2"  Dummy_FO
 SG_ CPSTOSConfAsmt : 21|12@0+ (1,0) [0|4095] ""  Dummy_FO
 SG_ CPSTOSNumCycTrkd : 4|3@0+ (1,0) [0|7] ""  Dummy_FO
 SG_ CPSTOSTimeToColl : 1|12@0+ (0.025,0) [0|102.375] "s"  Dummy_FO
 SG_ CPSTOSClosestInPthVehRng : 47|10@0+ (0.25,0) [0|255.75] "m"  Dummy_FO
 SG_ CPSTOSClosestInPthObID : 37|6@0+ (1,0) [0|63] "m"  Dummy_FO
 SG_ CPSTOSMeasStat : 39|2@0+ (1,0) [0|3] ""  Dummy_FO
 SG_ CPSTOSFuncState : 25|2@0+ (1,0) [0|3] ""  Dummy_FO

BO_ 1408 F_CPS_TOS_A: 8 EOCM_F_FO
 SG_ CPSTOSLongPos : 7|12@0- (0.125,0) [-256|255.875] "m"  Dummy_FO
 SG_ CPSTOSLatPos : 11|11@0- (0.125,0) [-128|127.875] "m"  Dummy_FO
 SG_ CPSTOSLongVel : 16|11@0- (0.125,0) [-128|127.875] "m/s"  Dummy_FO
 SG_ CPSTOSDynProp : 37|3@0+ (1,0) [0|7] ""  Dummy_FO
 SG_ CPSTOSLatVel : 34|11@0- (0.125,0) [-128|127.875] "m/s"  Dummy_FO
 SG_ CPSTOSARelLane : 63|2@0+ (1,0) [0|3] ""  Dummy_FO
 SG_ CPSTOSHiThrtID : 61|6@0+ (1,0) [0|63] ""  Dummy_FO
 SG_ CPSTOSHighestThreatObAsmt : 55|8@0+ (1,0) [0|255] ""  Dummy_FO

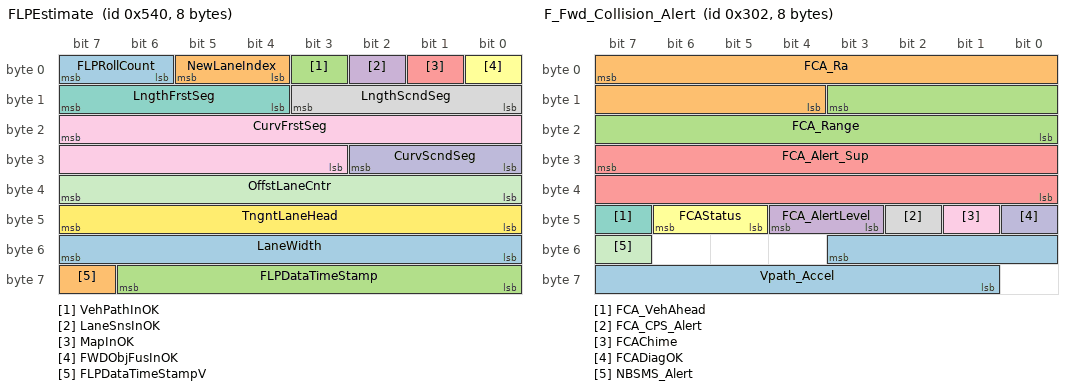
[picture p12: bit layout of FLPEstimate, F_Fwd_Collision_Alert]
BO_ 1344 FLPEstimate: 8 EOCM_F_FO
 SG_ FLPRollCount : 7|2@0+ (1,0) [0|3] ""  Dummy_FO
 SG_ NewLaneIndex : 5|2@0+ (1,0) [0|3] ""  Dummy_FO
 SG_ VehPathInOK : 3|1@0+ (1,0) [0|1] ""  Dummy_FO
 SG_ LaneSnsInOK : 2|1@0+ (1,0) [0|1] ""  Dummy_FO
 SG_ MapInOK : 1|1@0+ (1,0) [0|1] ""  Dummy_FO
 SG_ FWDObjFusInOK : 0|1@0+ (1,0) [0|1] ""  Dummy_FO
 SG_ LngthFrstSeg : 15|4@0+ (10,0) [0|150] "m"  Dummy_FO
 SG_ LngthScndSeg : 11|4@0+ (10,0) [0|150] "m"  Dummy_FO
 SG_ CurvFrstSeg : 23|13@0- (5E-005,0) [-0.2048|0.20475] "1/m"  Dummy_FO
 SG_ CurvScndSeg : 26|3@0- (0.001,0) [-0.004|0.003] "1/m"  Dummy_FO
 SG_ OffstLaneCntr : 39|8@0- (0.05,0) [-6.4|6.35] "m"  Dummy_FO
 SG_ TngntLaneHead : 47|8@0- (0.002,0) [-0.256|0.254] "m/m"  Dummy_FO
 SG_ LaneWidth : 55|8@0+ (0.05,0) [0|12.75] "m"  Dummy_FO
 SG_ FLPDataTimeStampV : 63|1@0+ (1,0) [0|1] ""  Dummy_FO
 SG_ FLPDataTimeStamp : 62|7@0+ (16,0) [0|2032] "ms"  Dummy_FO

BO_ 770 F_Fwd_Collision_Alert: 8 EOCM_F_FO
 SG_ Vpath_Accel : 51|11@0- (0.125,0) [-128|127.875] "m/s^2"  NVS_FO,Dummy_FO
 SG_ FCA_Ra : 7|12@0- (0.125,0) [-256|255.875] "m"  Dummy_FO
 SG_ FCA_Range : 11|12@0- (0.125,0) [-256|255.875] "m"  Dummy_FO
 SG_ FCA_AlertLevel : 44|2@0+ (1,0) [0|3] ""  Dummy_FO
 SG_ FCA_Alert_Sup : 31|16@0+ (1,0) [0|65535] ""  Dummy_FO
 SG_ FCAStatus : 46|2@0+ (1,0) [0|3] ""  Dummy_FO
 SG_ FCA_VehAhead : 47|1@0+ (1,0) [0|1] ""  Dummy_FO
 SG_ FCA_CPS_Alert : 42|1@0+ (1,0) [0|1] ""  Dummy_FO
 SG_ FCAChime : 41|1@0+ (1,0) [0|1] ""  Dummy_FO
 SG_ FCADiagOK : 40|1@0+ (1,0) [0|1] ""  Dummy_FO
 SG_ NBSMS_Alert : 55|1@0+ (1,0) [0|1] ""  Dummy_FO

BO_ 1601 USDT_Resp_From_VIS: 8 VIS_FO
 SG_ DgnInf_OBJ641 : 7|64@0+ (1,0) [0|1.84467440737096E+019] ""  TestTool_FO

BO_ 1606 USDT_Resp_From_RFSRR: 8 RFSRR_FO
 SG_ DgnInf_OBJ646 : 7|64@0+ (1,0) [0|1.84467440737096E+019] ""  TestTool_FO

BO_ 1603 USDT_Resp_From_LFSRR: 8 LFSRR_FO
 SG_ DgnInf_OBJ643 : 7|64@0+ (1,0) [0|1.84467440737096E+019] ""  TestTool_FO

BO_ 1602 USDT_Resp_From_LRR: 8 LRR_FO
 SG_ DgnInf_OBJ642 : 7|64@0+ (1,0) [0|1.84467440737096E+019] ""  TestTool_FO

BO_ 1625 USDT_Resp_From_RSRR: 8 RSRR_FO
 SG_ DgnInf_OBJ644 : 7|64@0+ (1,0) [0|1.84467440737096E+019] ""  TestTool_FO

BO_ 1611 USDT_Resp_From_FEOCM_FO: 8 EOCM_F_FO
 SG_ DgnInf_OBJ64B : 7|64@0+ (1,0) [0|1.84467440737096E+019] ""  TestTool_FO

BO_ 768 F_Smgr_Vehicle_Motion: 8 EOCM_F_FO
 SG_ SmgrMotRollAngle : 44|10@0- (0.1,0) [-51.2|51.1] "deg"  CIPM_FO,AMM_FO,EOCM2B_IMX6_FO,EOCM2B_K2_FO,EOCM2B_K1_FO,VIS_FO
 SG_ SmgrMotRollAngleV : 0|1@0+ (1,0) [0|1] ""  CIPM_FO,AMM_FO,EOCM2B_IMX6_FO,EOCM2B_K2_FO,EOCM2B_K1_FO,VIS_FO
 SG_ SmgrMotChecksum : 50|11@0+ (1,0) [0|2047] ""  CIPM_FO,AMM_FO,EOCM2B_IMX6_FO,EOCM2B_K2_FO,EOCM2B_K1_FO,VIS_FO
 SG_ SmgrMotPitchAngle : 39|11@0- (0.1,0) [-102.4|102.3] "deg"  CIPM_FO,NVS_FO,AMM_FO,EOCM2B_IMX6_FO,EOCM2B_K2_FO,EOCM2B_K1_FO,VIS_FO
 SG_ SmgrMotPitchAngleV : 1|1@0+ (1,0) [0|1] ""  CIPM_FO,NVS_FO,AMM_FO,EOCM2B_IMX6_FO,EOCM2B_K2_FO,EOCM2B_K1_FO,VIS_FO
 SG_ SmgrMotLongSpeedV : 2|1@0+ (1,0) [0|1] " "  CIPM_FO,AMM_FO,EOCM2B_IMX6_FO,EOCM2B_K2_FO,EOCM2B_K1_FO,VIS_FO
 SG_ SmgrMotLongSpeed : 18|11@0- (0.1,0) [-102.4|102.3] "m/s"  CIPM_FO,AMM_FO,EOCM2B_IMX6_FO,EOCM2B_K2_FO,EOCM2B_K1_FO,VIS_FO
 SG_ SmgrMotYawRate : 14|12@0- (0.05,0) [-102.4|102.35] "deg/s"  CIPM_FO,AMM_FO,EOCM2B_IMX6_FO,EOCM2B_K2_FO,EOCM2B_K1_FO,VIS_FO
 SG_ SmgrMotYawRateV : 15|1@0+ (1,0) [0|1] ""  CIPM_FO,AMM_FO,EOCM2B_IMX6_FO,EOCM2B_K2_FO,EOCM2B_K1_FO,VIS_FO
 SG_ SmgrMotRollingCnt : 4|2@0+ (1,0) [0|3] ""  CIPM_FO,AMM_FO,EOCM2B_IMX6_FO,EOCM2B_K2_FO,EOCM2B_K1_FO,VIS_FO

BO_ 1350 UUDT_Resp_From_RFSRR: 8 RFSRR_FO
 SG_ DgnInf_OBJ546 : 7|64@0+ (1,0) [0|1.84467440737096E+019] ""  TestTool_FO

BO_ 1369 UUDT_Resp_From_RSRR: 8 RSRR_FO
 SG_ DgnInf_OBJ544 : 7|64@0+ (1,0) [0|1.84467440737096E+019] ""  TestTool_FO

BO_ 1347 UUDT_Resp_From_LFSRR: 8 LFSRR_FO
 SG_ DgnInf_OBJ543 : 7|64@0+ (1,0) [0|1.84467440737096E+019] ""  TestTool_FO

BO_ 1346 UUDT_Resp_From_LRR: 8 LRR_FO
 SG_ DgnInf_OBJ542 : 7|64@0+ (1,0) [0|1.84467440737096E+019] ""  TestTool_FO

BO_ 1345 UUDT_Resp_From_VIS: 8 VIS_FO
 SG_ DgnInf_OBJ541 : 7|64@0+ (1,0) [0|1.84467440737096E+019] ""  TestTool_FO

BO_ 579 USDT_Req_to_LFSRR: 8 TestTool_FO
 SG_ DgnInf : 7|64@0+ (1,0) [0|1.84467440737096E+019] ""  LFSRR_FO

BO_ 577 USDT_Req_to_VIS: 8 TestTool_FO
 SG_ DgnInf : 7|64@0+ (1,0) [0|1.84467440737096E+019] ""  VIS_FO

BO_ 578 USDT_Req_to_LRR: 8 TestTool_FO
 SG_ DgnInf : 7|64@0+ (1,0) [0|1.84467440737096E+019] ""  LRR_FO

BO_ 582 USDT_Req_to_RFSRR: 8 TestTool_FO
 SG_ DgnInf : 7|64@0+ (1,0) [0|1.84467440737096E+019] ""  RFSRR_FO

BO_ 601 USDT_Req_to_RSRR: 8 TestTool_FO
 SG_ DgnInf : 7|64@0+ (1,0) [0|1.84467440737096E+019] ""  RSRR_FO

BO_ 1355 UUDT_Resp_From_FEOCM_FO: 8 EOCM_F_FO
 SG_ DgnInf_OBJ54B : 7|64@0+ (1,0) [0|1.84467440737096E+019] ""  TestTool_FO

BO_ 587 USDT_Req_to_FEOCM_obj: 8 TestTool_FO
 SG_ DgnInf : 7|64@0+ (1,0) [0|1.84467440737096E+019] ""  EOCM2A_K2_FO,EOCM_F_FO

BO_ 784 Body_Info_FOB: 6 EOCM_F_FO
 SG_ StrgColUpDwnPos : 39|8@0+ (1,0) [0|255] ""  DMS_FO
 SG_ CPMAPINFO4 : 47|1@0+ (1,0) [0|1] ""  DMS_FO
 SG_ StrgColInOutPos : 31|8@0+ (1,0) [0|255] ""  DMS_FO
 SG_ StrgColCommsFlt : 19|2@0+ (1,0) [0|3] ""  DMS_FO
 SG_ DrDoorOpenSwActV : 16|1@0+ (1,0) [0|1] ""  DMS_FO
 SG_ DrDoorOpenSwAct : 17|1@0+ (1,0) [0|1] ""  DMS_FO
 SG_ DrvWndPosStat : 22|3@0+ (1,0) [0|7] ""  CIPM_FO,DMS_FO,VIS2_FO,AMM_FO,EOCM2B_IMX6_FO,EOCM2B_K2_FO,EOCM2B_K1_FO
 SG_ InterLghtStat : 23|1@0+ (1,0) [0|1] ""  CIPM_FO,DMS_FO,VIS2_FO,AMM_FO,EOCM2B_IMX6_FO,EOCM2B_K2_FO,EOCM2B_K1_FO
 SG_ DrvrHndsOnWhlZn3 : 13|1@0+ (1,0) [0|1] ""  CIPM_FO,AMM_FO,DMS_FO,VIS2_FO,EOCM2B_IMX6_FO,EOCM2B_K2_FO,EOCM2B_K1_FO
 SG_ DrvrHndsOnWhlZn2 : 14|1@0+ (1,0) [0|1] ""  CIPM_FO,AMM_FO,EOCM2B_IMX6_FO,EOCM2B_K2_FO,EOCM2B_K1_FO,DMS_FO,VIS2_FO
 SG_ DrvrHndsOnWhlZn1 : 15|1@0+ (1,0) [0|1] ""  CIPM_FO,AMM_FO,EOCM2B_IMX6_FO,EOCM2B_K2_FO,EOCM2B_K1_FO,DMS_FO,VIS2_FO
 SG_ WSWshSwAtv : 11|1@0+ (1,0) [0|1] ""  CIPM_FO,EOCM2B_IMX6_FO,EOCM2B_K2_FO,EOCM2B_K1_FO,DMS_FO,AMM_FO,VIS_FO,VIS2_FO
 SG_ SysPwrMdV : 8|1@0+ (1,0) [0|1] ""  NVS_FO,RRSRR_FO,VIS_FO,RSRR_FO,RFSRR_FO,LRR_FO,LFSRR_FO,LRSRR_FO,CIPM_FO,_DOFIMU2_FO,_DOFIMU1_FO,DMS_FO,AMM_FO,EOCM2B_IMX6_FO,EOCM2B_K2_FO,EOCM2B_K1_FO,EOCM2A_IMX6_FO,EOCM2A_K2_FO,EOCM2A_K1_FO,VIS2_FO
 SG_ SysPwrMd : 10|2@0+ (1,0) [0|3] ""  NVS_FO,RRSRR_FO,VIS_FO,RSRR_FO,RFSRR_FO,LRR_FO,LFSRR_FO,LRSRR_FO,CIPM_FO,_DOFIMU2_FO,_DOFIMU1_FO,DMS_FO,AMM_FO,EOCM2B_IMX6_FO,EOCM2B_K2_FO,EOCM2B_K1_FO,EOCM2A_IMX6_FO,EOCM2A_K2_FO,EOCM2A_K1_FO,VIS2_FO
 SG_ WSWprAct : 2|1@0+ (1,0) [0|1] ""  CIPM_FO,EOCM2B_IMX6_FO,EOCM2B_K2_FO,EOCM2B_K1_FO,DMS_FO,AMM_FO,NVS_FO,VIS_FO,VIS2_FO
 SG_ RtLwBmFld : 4|1@0+ (1,0) [0|1] ""  CIPM_FO,EOCM2B_IMX6_FO,EOCM2B_K2_FO,EOCM2B_K1_FO,DMS_FO,AMM_FO,NVS_FO,VIS_FO,VIS2_FO
 SG_ OtsdAmbtLtLvlStatV : 5|1@0+ (1,0) [0|1] ""  CIPM_FO,EOCM2B_IMX6_FO,EOCM2B_K2_FO,EOCM2B_K1_FO,DMS_FO,AMM_FO,NVS_FO,VIS_FO,VIS2_FO
 SG_ OtsdAmbtLtLvlStat : 7|2@0+ (1,0) [0|3] ""  CIPM_FO,EOCM2B_IMX6_FO,EOCM2B_K2_FO,EOCM2B_K1_FO,DMS_FO,AMM_FO,NVS_FO,VIS_FO,VIS2_FO
 SG_ LowBmAct : 1|1@0+ (1,0) [0|1] ""  CIPM_FO,EOCM2B_IMX6_FO,EOCM2B_K2_FO,EOCM2B_K1_FO,DMS_FO,AMM_FO,NVS_FO,VIS_FO,VIS2_FO
 SG_ LftLwBmFld : 3|1@0+ (1,0) [0|1] ""  CIPM_FO,EOCM2B_IMX6_FO,EOCM2B_K2_FO,EOCM2B_K1_FO,DMS_FO,AMM_FO,NVS_FO,VIS_FO,VIS2_FO
 SG_ HighBmAct : 0|1@0+ (1,0) [0|1] ""  CIPM_FO,EOCM2B_IMX6_FO,EOCM2B_K2_FO,EOCM2B_K1_FO,DMS_FO,AMM_FO,NVS_FO,VIS_FO,VIS2_FO
 SG_ TrStLgMdAtv : 12|1@0+ (1,0) [0|1] ""  CIPM_FO,NVS_FO,RRSRR_FO,LRSRR_FO,_DOFIMU2_FO,_DOFIMU1_FO,DMS_FO,AMM_FO,EOCM2B_IMX6_FO,EOCM2B_K2_FO,EOCM2B_K1_FO,EOCM2A_IMX6_FO,EOCM2A_K2_FO,EOCM2A_K1_FO,LRR_FO,RFSRR_FO,LFSRR_FO,RSRR_FO,VIS_FO,VIS2_FO

BO_ 1539 RF_SRR_Trace_Data: 8 RFSRR_FO
 SG_ RFSRRYear : 7|8@0+ (1,0) [0|0] ""  EOCM_F_FO
 SG_ RFSRRSerialNmbr : 39|32@0+ (1,0) [0|0] ""  EOCM_F_FO
 SG_ RFSRRJulianDate : 15|24@0+ (1,0) [0|0] ""  EOCM_F_FO

BO_ 776 F_Vehicle_Path_Data_2: 7 EOCM_F_FO
 SG_ Vpath_Data2ModeInfo : 44|2@0+ (1,0) [0|3] ""  CIPM_FO,DMS_FO,AMM_FO,EOCM2B_IMX6_FO,EOCM2B_K2_FO,EOCM2B_K1_FO,VIS2_FO,RRSRR_FO,VIS_FO,RSRR_FO,RFSRR_FO,LRR_FO,LFSRR_FO
 SG_ Vpath2_Checksum : 42|11@0+ (1,0) [0|2047] ""  CIPM_FO,DMS_FO,AMM_FO,EOCM2B_IMX6_FO,EOCM2B_K2_FO,EOCM2B_K1_FO,VIS2_FO,RRSRR_FO,VIS_FO,RFSRR_FO,LFSRR_FO,RSRR_FO,LRR_FO
 SG_ Vpath_Data2RollCnt : 46|2@0+ (1,0) [0|3] ""  CIPM_FO,DMS_FO,AMM_FO,EOCM2B_IMX6_FO,EOCM2B_K2_FO,EOCM2B_K1_FO,VIS2_FO,RRSRR_FO,VIS_FO,RSRR_FO,RFSRR_FO,LRR_FO,LFSRR_FO
 SG_ Vpath_Data2YawRateV : 2|1@0+ (1,0) [0|1] ""  CIPM_FO,DMS_FO,AMM_FO,EOCM2B_IMX6_FO,EOCM2B_K2_FO,EOCM2B_K1_FO,VIS2_FO,NVS_FO,RRSRR_FO,VIS_FO,RSRR_FO,RFSRR_FO,LRR_FO,LFSRR_FO
 SG_ Vpath_Data2LongVelV : 1|1@0+ (1,0) [0|1] ""  CIPM_FO,DMS_FO,AMM_FO,EOCM2B_IMX6_FO,EOCM2B_K2_FO,EOCM2B_K1_FO,VIS2_FO,RRSRR_FO,NVS_FO,VIS_FO,RSRR_FO,RFSRR_FO,LRR_FO,LFSRR_FO
 SG_ Vpath_Data2LatVelV : 47|1@0+ (1,0) [0|1] ""  CIPM_FO,DMS_FO,AMM_FO,EOCM2B_IMX6_FO,EOCM2B_K2_FO,EOCM2B_K1_FO,VIS2_FO,RRSRR_FO,VIS_FO,RSRR_FO,RFSRR_FO,LRR_FO,LFSRR_FO
 SG_ Vpath_Data2TravlDirctn : 4|2@0+ (1,0) [0|3] ""  CIPM_FO,DMS_FO,AMM_FO,EOCM2B_IMX6_FO,EOCM2B_K2_FO,EOCM2B_K1_FO,VIS2_FO,RRSRR_FO,VIS_FO,RSRR_FO,RFSRR_FO,LRR_FO,LFSRR_FO
 SG_ Vpath_Data2LongVel : 15|12@0- (0.0625,0) [-128|127.9375] "m/s"  CIPM_FO,DMS_FO,AMM_FO,EOCM2B_IMX6_FO,EOCM2B_K2_FO,EOCM2B_K1_FO,VIS2_FO,RRSRR_FO,NVS_FO,VIS_FO,RSRR_FO,RFSRR_FO,LRR_FO,LFSRR_FO
 SG_ Vpath_Data2YawRate : 19|12@0- (0.0625,0) [-128|127.9375] "deg/s"  CIPM_FO,DMS_FO,AMM_FO,EOCM2B_IMX6_FO,EOCM2B_K2_FO,EOCM2B_K1_FO,VIS2_FO,NVS_FO,RRSRR_FO,VIS_FO,RSRR_FO,RFSRR_FO,LRR_FO,LFSRR_FO
 SG_ Vpath_Data2LatVel : 39|8@0- (0.05,0) [-6.4|6.35] "m/s"  CIPM_FO,DMS_FO,AMM_FO,EOCM2B_IMX6_FO,EOCM2B_K2_FO,EOCM2B_K1_FO,VIS2_FO,RRSRR_FO,VIS_FO,RSRR_FO,RFSRR_FO,LRR_FO,LFSRR_FO

BO_ 161 F_Master_Time_Sync: 7 EOCM_F_FO
 SG_ FTimeSyncMstrChksm : 35|12@0+ (1,0) [0|4095] ""  AMM_FO,CIPM_FO,EOCM2B_IMX6_FO,EOCM2B_K2_FO,EOCM2B_K1_FO,VIS2_FO,RRSRR_FO,VIS_FO,RSRR_FO,RFSRR_FO,LRR_FO,LFSRR_FO
 SG_ FTimeSyncMstrClock : 7|32@0+ (1,0) [0|4294967295] "ms"  CIPM_FO,AMM_FO,EOCM2B_IMX6_FO,EOCM2B_K2_FO,EOCM2B_K1_FO,VIS2_FO,RRSRR_FO,VIS_FO,RSRR_FO,RFSRR_FO,LRR_FO,LFSRR_FO
 SG_ SensorModeCmdLRR : 39|3@0+ (1,0) [0|7] ""  CIPM_FO,EOCM2B_IMX6_FO,EOCM2B_K2_FO,EOCM2B_K1_FO,VIS2_FO,RRSRR_FO,VIS_FO,RSRR_FO,RFSRR_FO,LRR_FO,LFSRR_FO
 SG_ SensorModeCmdSRR : 50|3@0+ (1,0) [0|7] ""  CIPM_FO,EOCM2B_IMX6_FO,EOCM2B_K2_FO,EOCM2B_K1_FO,VIS2_FO,RRSRR_FO,VIS_FO,RSRR_FO,RFSRR_FO,LRR_FO,LFSRR_FO
 SG_ SensorModeCmdFCamera : 53|3@0+ (1,0) [0|7] ""  CIPM_FO,EOCM2B_IMX6_FO,EOCM2B_K2_FO,EOCM2B_K1_FO,VIS2_FO,RRSRR_FO,VIS_FO,RSRR_FO,RFSRR_FO,LRR_FO,LFSRR_FO
 SG_ FTimeSyncMstrClockV : 36|1@0+ (1,0) [0|1] ""  CIPM_FO,AMM_FO,EOCM2B_IMX6_FO,EOCM2B_K2_FO,EOCM2B_K1_FO,VIS2_FO,RRSRR_FO,VIS_FO,RSRR_FO,LRR_FO,RFSRR_FO,LFSRR_FO

BO_ 774 F_Vehicle_Path_Estimate: 8 EOCM_F_FO
 SG_ Vpath_RollingCount : 7|2@0+ (1,0) [0|3] ""  CIPM_FO,AMM_FO,EOCM2B_IMX6_FO,EOCM2B_K2_FO,EOCM2B_K1_FO,VIS2_FO,RRSRR_FO,VIS_FO,RSRR_FO,RFSRR_FO,LRR_FO,LFSRR_FO
 SG_ Vpath_TrnCtrLngOfstV : 1|1@0+ (1,0) [0|1] ""  CIPM_FO,AMM_FO,EOCM2B_IMX6_FO,EOCM2B_K2_FO,EOCM2B_K1_FO,VIS2_FO,RRSRR_FO,LRR_FO,VIS_FO,RSRR_FO,RFSRR_FO,LFSRR_FO
 SG_ Vpath_Checksum : 50|11@0+ (1,0) [0|2047] ""  CIPM_FO,AMM_FO,EOCM2B_IMX6_FO,EOCM2B_K2_FO,EOCM2B_K1_FO,VIS2_FO,RRSRR_FO,VIS_FO,RSRR_FO,RFSRR_FO,LRR_FO,LFSRR_FO
 SG_ Vpath_TrnCtrLngOfst : 15|8@0- (0.1,0) [-12.8|12.7] "m"  CIPM_FO,AMM_FO,EOCM2B_IMX6_FO,EOCM2B_K2_FO,EOCM2B_K1_FO,VIS2_FO,RRSRR_FO,LRR_FO,VIS_FO,RSRR_FO,RFSRR_FO,LFSRR_FO
 SG_ Vpath_TrnCtrLatOfst : 21|14@0- (1,0) [-8192|8191] "m"  CIPM_FO,AMM_FO,EOCM2B_IMX6_FO,EOCM2B_K2_FO,EOCM2B_K1_FO,VIS2_FO,RRSRR_FO,LRR_FO,VIS_FO,RSRR_FO,RFSRR_FO,LFSRR_FO
 SG_ Vpath_Curvature : 39|16@0- (1E-005,0) [-0.32768|0.32767] "1/m"  CIPM_FO,AMM_FO,EOCM2B_IMX6_FO,EOCM2B_K2_FO,EOCM2B_K1_FO,VIS2_FO,RRSRR_FO,VIS_FO,RSRR_FO,RFSRR_FO,LRR_FO,LFSRR_FO
 SG_ Vpath_CurvatureV : 0|1@0+ (1,0) [0|1] ""  CIPM_FO,AMM_FO,EOCM2B_IMX6_FO,EOCM2B_K2_FO,EOCM2B_K1_FO,VIS2_FO,RRSRR_FO,VIS_FO,LRR_FO,RSRR_FO,RFSRR_FO,LFSRR_FO

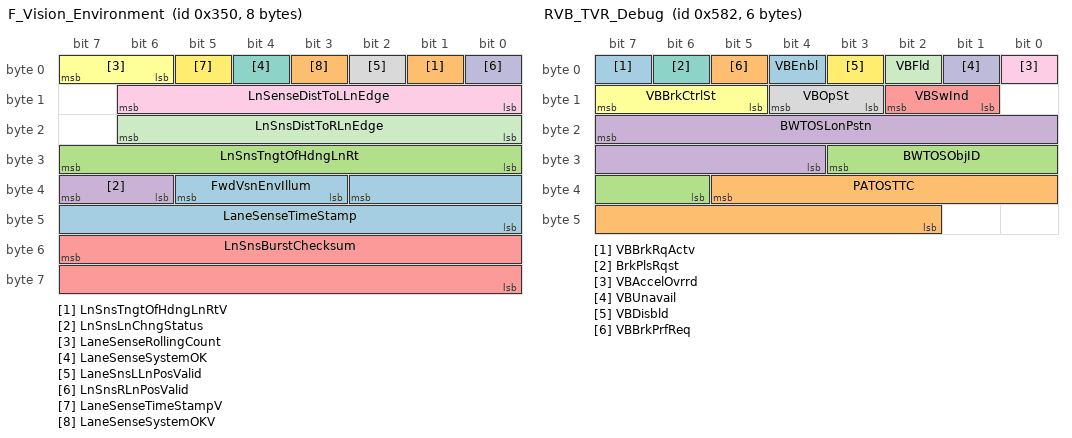
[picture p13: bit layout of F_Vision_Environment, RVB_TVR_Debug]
BO_ 848 F_Vision_Environment: 8 VIS_FO
 SG_ FwdVsnEnvIllum : 37|3@0+ (1,0) [0|7] ""  EOCM2A_IMX6_FO,EOCM2A_K2_FO,EOCM2A_K1_FO,EOCM2B_IMX6_FO,EOCM2B_K2_FO,EOCM2B_K1_FO,EOCM_F_FO
 SG_ LnSnsTngtOfHdngLnRtV : 1|1@0+ (1,0) [0|1] ""  EOCM2A_IMX6_FO,EOCM2A_K2_FO,EOCM2A_K1_FO,EOCM2B_IMX6_FO,EOCM2B_K2_FO,EOCM2B_K1_FO,EOCM_F_FO
 SG_ LnSnsTngtOfHdngLnRt : 31|8@0- (0.002,0) [-0.256|0.254] "m/m"  EOCM2A_IMX6_FO,EOCM2A_K2_FO,EOCM2A_K1_FO,EOCM2B_IMX6_FO,EOCM2B_K2_FO,EOCM2B_K1_FO,EOCM_F_FO
 SG_ LnSnsLnChngStatus : 39|2@0+ (1,0) [0|3] ""  EOCM2A_IMX6_FO,EOCM2A_K2_FO,EOCM2A_K1_FO,EOCM2B_IMX6_FO,EOCM2B_K2_FO,EOCM2B_K1_FO,EOCM_F_FO
 SG_ LnSnsBurstChecksum : 55|16@0+ (1,0) [0|65535] ""  EOCM2A_IMX6_FO,EOCM2A_K2_FO,EOCM2A_K1_FO,EOCM2B_IMX6_FO,EOCM2B_K2_FO,EOCM2B_K1_FO,EOCM_F_FO
 SG_ LaneSenseRollingCount : 7|2@0+ (1,0) [0|3] ""  EOCM2A_IMX6_FO,EOCM2A_K2_FO,EOCM2A_K1_FO,EOCM2B_IMX6_FO,EOCM2B_K2_FO,EOCM2B_K1_FO,EOCM_F_FO
 SG_ LaneSenseSystemOK : 4|1@0+ (1,0) [0|1] ""  EOCM2A_IMX6_FO,EOCM2A_K2_FO,EOCM2A_K1_FO,EOCM2B_IMX6_FO,EOCM2B_K2_FO,EOCM2B_K1_FO,EOCM_F_FO
 SG_ LaneSnsLLnPosValid : 2|1@0+ (1,0) [0|1] ""  EOCM2A_IMX6_FO,EOCM2A_K2_FO,EOCM2A_K1_FO,EOCM2B_IMX6_FO,EOCM2B_K2_FO,EOCM2B_K1_FO,EOCM_F_FO
 SG_ LnSenseDistToLLnEdge : 14|7@0+ (0.05,0) [0|6.35] "m"  EOCM2A_IMX6_FO,EOCM2A_K2_FO,EOCM2A_K1_FO,EOCM2B_IMX6_FO,EOCM2B_K2_FO,EOCM2B_K1_FO,EOCM_F_FO
 SG_ LnSnsRLnPosValid : 0|1@0+ (1,0) [0|1] ""  EOCM2A_IMX6_FO,EOCM2A_K2_FO,EOCM2A_K1_FO,EOCM2B_IMX6_FO,EOCM2B_K2_FO,EOCM2B_K1_FO,EOCM_F_FO
 SG_ LnSnsDistToRLnEdge : 22|7@0+ (0.05,0) [0|6.35] "m"  EOCM2A_IMX6_FO,EOCM2A_K2_FO,EOCM2A_K1_FO,EOCM2B_IMX6_FO,EOCM2B_K2_FO,EOCM2B_K1_FO,EOCM_F_FO
 SG_ LaneSenseTimeStampV : 5|1@0+ (1,0) [0|1] ""  EOCM2A_IMX6_FO,EOCM2A_K2_FO,EOCM2A_K1_FO,EOCM2B_IMX6_FO,EOCM2B_K2_FO,EOCM2B_K1_FO,EOCM_F_FO
 SG_ LaneSenseTimeStamp : 34|11@0+ (1,0) [0|2047] "ms"  EOCM2A_IMX6_FO,EOCM2A_K2_FO,EOCM2A_K1_FO,EOCM2B_IMX6_FO,EOCM2B_K2_FO,EOCM2B_K1_FO,EOCM_F_FO
 SG_ LaneSenseSystemOKV : 3|1@0+ (1,0) [0|1] ""  EOCM2A_IMX6_FO,EOCM2A_K2_FO,EOCM2A_K1_FO,EOCM2B_IMX6_FO,EOCM2B_K2_FO,EOCM2B_K1_FO,EOCM_F_FO

BO_ 849 F_Vision_Environment_2: 8 VIS_FO
 SG_ LnSnsLatVRelToRgtMrkg : 23|8@0- (0.02,0) [-2.56|2.54] "m/s"  EOCM2A_IMX6_FO,EOCM2A_K2_FO,EOCM2A_K1_FO,EOCM_F_FO,EOCM2B_IMX6_FO,EOCM2B_K2_FO,EOCM2B_K1_FO
 SG_ LnSnsRtLnMrkgTypChgDst : 61|4@0+ (10,0) [0|150] "m"  EOCM2A_IMX6_FO,EOCM2A_K2_FO,EOCM2A_K1_FO,EOCM2B_IMX6_FO,EOCM2B_K2_FO,EOCM2B_K1_FO,EOCM_F_FO
 SG_ LnSnsCrvtGrdntRtV : 63|1@0+ (1,0) [0|1] ""  EOCM2A_IMX6_FO,EOCM2A_K2_FO,EOCM2A_K1_FO,EOCM2B_IMX6_FO,EOCM2B_K2_FO,EOCM2B_K1_FO,EOCM_F_FO
 SG_ LnSnsLnMrkgWdthRt : 62|1@0+ (1,0) [0|1] ""  EOCM2A_IMX6_FO,EOCM2A_K2_FO,EOCM2A_K1_FO,EOCM2B_IMX6_FO,EOCM2B_K2_FO,EOCM2B_K1_FO,EOCM_F_FO
 SG_ LnSnsRtAnchrLn : 57|1@0+ (1,0) [0|1] ""  EOCM2A_IMX6_FO,EOCM2A_K2_FO,EOCM2A_K1_FO,EOCM2B_IMX6_FO,EOCM2B_K2_FO,EOCM2B_K1_FO,EOCM_F_FO
 SG_ LnSnsLtAnchrLn : 56|1@0+ (1,0) [0|1] ""  EOCM2A_IMX6_FO,EOCM2A_K2_FO,EOCM2A_K1_FO,EOCM2B_IMX6_FO,EOCM2B_K2_FO,EOCM2B_K1_FO,EOCM_F_FO
 SG_ LnSnsLnCrvtrRghtV : 0|1@0+ (1,0) [0|1] ""  EOCM2A_IMX6_FO,EOCM2A_K2_FO,EOCM2A_K1_FO,EOCM2B_IMX6_FO,EOCM2B_K2_FO,EOCM2B_K1_FO,EOCM_F_FO
 SG_ LnSnsLnCrvtrRght : 47|16@0- (9.53E-007,0) [-0.031227904|0.031226951] "1/m"  EOCM2A_IMX6_FO,EOCM2A_K2_FO,EOCM2A_K1_FO,EOCM2B_IMX6_FO,EOCM2B_K2_FO,EOCM2B_K1_FO,EOCM_F_FO
 SG_ LnSnsCrvtGrdntRt : 31|16@0- (5.96E-008,0) [-0.0019529728|0.0019529132] "1/rad/s"  EOCM2A_IMX6_FO,EOCM2A_K2_FO,EOCM2A_K1_FO,EOCM2B_IMX6_FO,EOCM2B_K2_FO,EOCM2B_K1_FO,EOCM_F_FO
 SG_ LnSnsBurstID : 2|2@0+ (1,0) [0|3] ""  EOCM2A_IMX6_FO,EOCM2A_K2_FO,EOCM2A_K1_FO,EOCM2B_IMX6_FO,EOCM2B_K2_FO,EOCM2B_K1_FO,EOCM_F_FO
 SG_ LnSnsLatVRelToLftMrkg : 15|8@0- (0.02,0) [-2.56|2.54] "m/s"  EOCM2A_IMX6_FO,EOCM2A_K2_FO,EOCM2A_K1_FO,EOCM2B_IMX6_FO,EOCM2B_K2_FO,EOCM2B_K1_FO,EOCM_F_FO

BO_ 1184 R_SRR_Object_Header: 8 RSRR_FO
 SG_ RSRRNumValidTargets : 14|4@0+ (1,0) [0|15] ""  EOCM_F_FO
 SG_ RSrrRollingCnt : 1|2@0+ (1,0) [0|3] ""  EOCM_F_FO
 SG_ RSRRModeCmdFdbk : 4|3@0+ (1,0) [0|7] ""  EOCM_F_FO
 SG_ RSrrTimeStampV : 15|1@0+ (1,0) [0|1] ""  EOCM_F_FO
 SG_ RSrrTimeStamp : 10|11@0+ (1,0) [0|2047] "ms"  EOCM_F_FO
 SG_ RSrrBurstChecksum : 55|16@0+ (1,0) [0|65535] ""  EOCM_F_FO
 SG_ RSRRSnstvFltPrsntInt : 24|1@0+ (1,0) [0|1] ""  EOCM_F_FO
 SG_ RSRRPlntAlgnInProc : 37|1@0+ (1,0) [0|1] ""  EOCM_F_FO
 SG_ RSRRMsalgnYawRt : 47|1@0+ (1,0) [0|1] ""  EOCM_F_FO
 SG_ RSRRMsalgnYawLt : 46|1@0+ (1,0) [0|1] ""  EOCM_F_FO
 SG_ RSRRMsalgnRllRt : 35|1@0+ (1,0) [0|1] ""  EOCM_F_FO
 SG_ RSRRMsalgnRllLt : 34|1@0+ (1,0) [0|1] ""  EOCM_F_FO
 SG_ RSRRMsalgnPtchUp : 32|1@0+ (1,0) [0|1] ""  EOCM_F_FO
 SG_ RSRRMsalgnPtchDn : 33|1@0+ (1,0) [0|1] ""  EOCM_F_FO
 SG_ RSRRInitDiagCmplt : 40|1@0+ (1,0) [0|1] ""  EOCM_F_FO
 SG_ RSRRHWFltPrsntInt : 25|1@0+ (1,0) [0|1] ""  EOCM_F_FO
 SG_ RSRRExtIntrfrnc : 36|1@0+ (1,0) [0|1] ""  EOCM_F_FO
 SG_ RSRRDiagSpare : 30|1@0+ (1,0) [0|1] ""  EOCM_F_FO
 SG_ RSRRCANSgnlSpvFld : 29|1@0+ (1,0) [0|1] ""  EOCM_F_FO
 SG_ RSRRCANRxErr : 28|1@0+ (1,0) [0|1] ""  EOCM_F_FO
 SG_ RSRRCANIDAddrsUnsbl : 27|1@0+ (1,0) [0|1] ""  EOCM_F_FO
 SG_ RSRRAntTngFltPrsnt : 26|1@0+ (1,0) [0|1] ""  EOCM_F_FO
 SG_ RSRRAmbTmpOutRngLw : 42|1@0+ (1,0) [0|1] ""  EOCM_F_FO
 SG_ RSRRAmbTmpOutRngHi : 41|1@0+ (1,0) [0|1] ""  EOCM_F_FO
 SG_ RSRRAlgnFltPrsnt : 39|1@0+ (1,0) [0|1] ""  EOCM_F_FO
 SG_ RSRRVltgOutRngLo : 44|1@0+ (1,0) [0|1] ""  EOCM_F_FO
 SG_ RSRRVltgOutRngHi : 43|1@0+ (1,0) [0|1] ""  EOCM_F_FO
 SG_ RSRRSvcAlgnInPrcs : 38|1@0+ (1,0) [0|1] ""  EOCM_F_FO
 SG_ RSRRSnsrBlckd : 45|1@0+ (1,0) [0|1] ""  EOCM_F_FO

BO_ 1185 R_SRR_Object_Track1: 8 RSRR_FO
 SG_ RSrrBurstID1 : 63|2@0+ (1,0) [0|3] ""  EOCM_F_FO
 SG_ RSrrTrkRange1 : 2|11@0+ (0.02,0) [0|40.94] "m"  EOCM_F_FO
 SG_ RSrrTrkRRate1 : 18|11@0- (0.125,0) [-128|127.875] "m/s"  EOCM_F_FO
 SG_ RSrrTrkAzimuth1 : 34|11@0- (0.125,0) [-128|127.875] "deg"  EOCM_F_FO
 SG_ RSrrTrkObjID1 : 39|5@0+ (1,0) [0|31] ""  EOCM_F_FO
 SG_ RSrrTrkObjElevation1 : 20|2@0+ (1,0) [0|3] ""  EOCM_F_FO
 SG_ RSrrTrkDynamProp1 : 23|3@0+ (1,0) [0|7] ""  EOCM_F_FO
 SG_ RSrrTrkMeasStatus1 : 55|2@0+ (1,0) [0|3] ""  EOCM_F_FO
 SG_ RSrrTrkObsRange1 : 53|6@0- (0.02,0) [-0.64|0.62] "m"  EOCM_F_FO
 SG_ RSrrTrkRawAzimuth1 : 61|6@0- (1,0) [-32|31] "deg"  EOCM_F_FO

BO_ 1186 R_SRR_Object_Track2: 8 RSRR_FO
 SG_ RSrrBurstID2 : 63|2@0+ (1,0) [0|3] ""  EOCM_F_FO
 SG_ RSrrTrkRange2 : 2|11@0+ (0.02,0) [0|40.94] "m"  EOCM_F_FO
 SG_ RSrrTrkRRate2 : 18|11@0- (0.125,0) [-128|127.875] "m/s"  EOCM_F_FO
 SG_ RSrrTrkAzimuth2 : 34|11@0- (0.125,0) [-128|127.875] "deg"  EOCM_F_FO
 SG_ RSrrTrkObjID2 : 39|5@0+ (1,0) [0|31] ""  EOCM_F_FO
 SG_ RSrrTrkObjElevation2 : 20|2@0+ (1,0) [0|3] ""  EOCM_F_FO
 SG_ RSrrTrkDynamProp2 : 23|3@0+ (1,0) [0|7] ""  EOCM_F_FO
 SG_ RSrrTrkMeasStatus2 : 55|2@0+ (1,0) [0|3] ""  EOCM_F_FO
 SG_ RSrrTrkObsRange2 : 53|6@0- (0.02,0) [-0.64|0.62] "m"  EOCM_F_FO
 SG_ RSrrTrkRawAzimuth2 : 61|6@0- (1,0) [-32|31] "deg"  EOCM_F_FO

BO_ 1187 R_SRR_Object_Track3: 8 RSRR_FO
 SG_ RSrrBurstID3 : 63|2@0+ (1,0) [0|3] ""  EOCM_F_FO
 SG_ RSrrTrkRange3 : 2|11@0+ (0.02,0) [0|40.94] "m"  EOCM_F_FO
 SG_ RSrrTrkRRate3 : 18|11@0- (0.125,0) [-128|127.875] "m/s"  EOCM_F_FO
 SG_ RSrrTrkAzimuth3 : 34|11@0- (0.125,0) [-128|127.875] "deg"  EOCM_F_FO
 SG_ RSrrTrkObjID3 : 39|5@0+ (1,0) [0|31] ""  EOCM_F_FO
 SG_ RSrrTrkObjElevation3 : 20|2@0+ (1,0) [0|3] ""  EOCM_F_FO
 SG_ RSrrTrkDynamProp3 : 23|3@0+ (1,0) [0|7] ""  EOCM_F_FO
 SG_ RSrrTrkMeasStatus3 : 55|2@0+ (1,0) [0|3] ""  EOCM_F_FO
 SG_ RSrrTrkObsRange3 : 53|6@0- (0.02,0) [-0.64|0.62] "m"  EOCM_F_FO
 SG_ RSrrTrkRawAzimuth3 : 61|6@0- (1,0) [-32|31] "deg"  EOCM_F_FO

BO_ 1188 R_SRR_Object_Track4: 8 RSRR_FO
 SG_ RSrrBurstID4 : 63|2@0+ (1,0) [0|3] ""  EOCM_F_FO
 SG_ RSrrTrkRange4 : 2|11@0+ (0.02,0) [0|40.94] "m"  EOCM_F_FO
 SG_ RSrrTrkRRate4 : 18|11@0- (0.125,0) [-128|127.875] "m/s"  EOCM_F_FO
 SG_ RSrrTrkAzimuth4 : 34|11@0- (0.125,0) [-128|127.875] "deg"  EOCM_F_FO
 SG_ RSrrTrkObjID4 : 39|5@0+ (1,0) [0|31] ""  EOCM_F_FO
 SG_ RSrrTrkObjElevation4 : 20|2@0+ (1,0) [0|3] ""  EOCM_F_FO
 SG_ RSrrTrkDynamProp4 : 23|3@0+ (1,0) [0|7] ""  EOCM_F_FO
 SG_ RSrrTrkMeasStatus4 : 55|2@0+ (1,0) [0|3] ""  EOCM_F_FO
 SG_ RSrrTrkObsRange4 : 53|6@0- (0.02,0) [-0.64|0.62] "m"  EOCM_F_FO
 SG_ RSrrTrkRawAzimuth4 : 61|6@0- (1,0) [-32|31] "deg"  EOCM_F_FO

BO_ 1189 R_SRR_Object_Track5: 8 RSRR_FO
 SG_ RSrrBurstID5 : 63|2@0+ (1,0) [0|3] ""  EOCM_F_FO
 SG_ RSrrTrkRange5 : 2|11@0+ (0.02,0) [0|40.94] "m"  EOCM_F_FO
 SG_ RSrrTrkRRate5 : 18|11@0- (0.125,0) [-128|127.875] "m/s"  EOCM_F_FO
 SG_ RSrrTrkAzimuth5 : 34|11@0- (0.125,0) [-128|127.875] "deg"  EOCM_F_FO
 SG_ RSrrTrkObjID5 : 39|5@0+ (1,0) [0|31] ""  EOCM_F_FO
 SG_ RSrrTrkObjElevation5 : 20|2@0+ (1,0) [0|3] ""  EOCM_F_FO
 SG_ RSrrTrkDynamProp5 : 23|3@0+ (1,0) [0|7] ""  EOCM_F_FO
 SG_ RSrrTrkMeasStatus5 : 55|2@0+ (1,0) [0|3] ""  EOCM_F_FO
 SG_ RSrrTrkObsRange5 : 53|6@0- (0.02,0) [-0.64|0.62] "m"  EOCM_F_FO
 SG_ RSrrTrkRawAzimuth5 : 61|6@0- (1,0) [-32|31] "deg"  EOCM_F_FO

BO_ 1190 R_SRR_Object_Track6: 8 RSRR_FO
 SG_ RSrrBurstID6 : 63|2@0+ (1,0) [0|3] ""  EOCM_F_FO
 SG_ RSrrTrkRange6 : 2|11@0+ (0.02,0) [0|40.94] "m"  EOCM_F_FO
 SG_ RSrrTrkRRate6 : 18|11@0- (0.125,0) [-128|127.875] "m/s"  EOCM_F_FO
 SG_ RSrrTrkAzimuth6 : 34|11@0- (0.125,0) [-128|127.875] "deg"  EOCM_F_FO
 SG_ RSrrTrkObjID6 : 39|5@0+ (1,0) [0|31] ""  EOCM_F_FO
 SG_ RSrrTrkObjElevation6 : 20|2@0+ (1,0) [0|3] ""  EOCM_F_FO
 SG_ RSrrTrkDynamProp6 : 23|3@0+ (1,0) [0|7] ""  EOCM_F_FO
 SG_ RSrrTrkMeasStatus6 : 55|2@0+ (1,0) [0|3] ""  EOCM_F_FO
 SG_ RSrrTrkObsRange6 : 53|6@0- (0.02,0) [-0.64|0.62] "m"  EOCM_F_FO
 SG_ RSrrTrkRawAzimuth6 : 61|6@0- (1,0) [-32|31] "deg"  EOCM_F_FO

BO_ 1191 R_SRR_Object_Track7: 8 RSRR_FO
 SG_ RSrrBurstID7 : 63|2@0+ (1,0) [0|3] ""  EOCM_F_FO
 SG_ RSrrTrkRange7 : 2|11@0+ (0.02,0) [0|40.94] "m"  EOCM_F_FO
 SG_ RSrrTrkRRate7 : 18|11@0- (0.125,0) [-128|127.875] "m/s"  EOCM_F_FO
 SG_ RSrrTrkAzimuth7 : 34|11@0- (0.125,0) [-128|127.875] "deg"  EOCM_F_FO
 SG_ RSrrTrkObjID7 : 39|5@0+ (1,0) [0|31] ""  EOCM_F_FO
 SG_ RSrrTrkObjElevation7 : 20|2@0+ (1,0) [0|3] ""  EOCM_F_FO
 SG_ RSrrTrkDynamProp7 : 23|3@0+ (1,0) [0|7] ""  EOCM_F_FO
 SG_ RSrrTrkMeasStatus7 : 55|2@0+ (1,0) [0|3] ""  EOCM_F_FO
 SG_ RSrrTrkObsRange7 : 53|6@0- (0.02,0) [-0.64|0.62] "m"  EOCM_F_FO
 SG_ RSrrTrkRawAzimuth7 : 61|6@0- (1,0) [-32|31] "deg"  EOCM_F_FO

BO_ 1192 R_SRR_Object_Track8: 8 RSRR_FO
 SG_ RSrrBurstID8 : 63|2@0+ (1,0) [0|3] ""  EOCM_F_FO
 SG_ RSrrTrkRange8 : 2|11@0+ (0.02,0) [0|40.94] "m"  EOCM_F_FO
 SG_ RSrrTrkRRate8 : 18|11@0- (0.125,0) [-128|127.875] "m/s"  EOCM_F_FO
 SG_ RSrrTrkAzimuth8 : 34|11@0- (0.125,0) [-128|127.875] "deg"  EOCM_F_FO
 SG_ RSrrTrkObjID8 : 39|5@0+ (1,0) [0|31] ""  EOCM_F_FO
 SG_ RSrrTrkObjElevation8 : 20|2@0+ (1,0) [0|3] ""  EOCM_F_FO
 SG_ RSrrTrkDynamProp8 : 23|3@0+ (1,0) [0|7] ""  EOCM_F_FO
 SG_ RSrrTrkMeasStatus8 : 55|2@0+ (1,0) [0|3] ""  EOCM_F_FO
 SG_ RSrrTrkObsRange8 : 53|6@0- (0.02,0) [-0.64|0.62] "m"  EOCM_F_FO
 SG_ RSrrTrkRawAzimuth8 : 61|6@0- (1,0) [-32|31] "deg"  EOCM_F_FO

BO_ 1193 R_SRR_Object_Track9: 8 RSRR_FO
 SG_ RSrrBurstID9 : 63|2@0+ (1,0) [0|3] ""  EOCM_F_FO
 SG_ RSrrTrkRange9 : 2|11@0+ (0.02,0) [0|40.94] "m"  EOCM_F_FO
 SG_ RSrrTrkRRate9 : 18|11@0- (0.125,0) [-128|127.875] "m/s"  EOCM_F_FO
 SG_ RSrrTrkAzimuth9 : 34|11@0- (0.125,0) [-128|127.875] "deg"  EOCM_F_FO
 SG_ RSrrTrkObjID9 : 39|5@0+ (1,0) [0|31] ""  EOCM_F_FO
 SG_ RSrrTrkObjElevation9 : 20|2@0+ (1,0) [0|3] ""  EOCM_F_FO
 SG_ RSrrTrkDynamProp9 : 23|3@0+ (1,0) [0|7] ""  EOCM_F_FO
 SG_ RSrrTrkMeasStatus9 : 55|2@0+ (1,0) [0|3] ""  EOCM_F_FO
 SG_ RSrrTrkObsRange9 : 53|6@0- (0.02,0) [-0.64|0.62] "m"  EOCM_F_FO
 SG_ RSrrTrkRawAzimuth9 : 61|6@0- (1,0) [-32|31] "deg"  EOCM_F_FO

BO_ 1194 R_SRR_Object_Track10: 8 RSRR_FO
 SG_ RSrrBurstID10 : 63|2@0+ (1,0) [0|3] ""  EOCM_F_FO
 SG_ RSrrTrkRange10 : 2|11@0+ (0.02,0) [0|40.94] "m"  EOCM_F_FO
 SG_ RSrrTrkRRate10 : 18|11@0- (0.125,0) [-128|127.875] "m/s"  EOCM_F_FO
 SG_ RSrrTrkAzimuth10 : 34|11@0- (0.125,0) [-128|127.875] "deg"  EOCM_F_FO
 SG_ RSrrTrkObjID10 : 39|5@0+ (1,0) [0|31] ""  EOCM_F_FO
 SG_ RSrrTrkObjElevation10 : 20|2@0+ (1,0) [0|3] ""  EOCM_F_FO
 SG_ RSrrTrkDynamProp10 : 23|3@0+ (1,0) [0|7] ""  EOCM_F_FO
 SG_ RSrrTrkMeasStatus10 : 55|2@0+ (1,0) [0|3] ""  EOCM_F_FO
 SG_ RSrrTrkObsRange10 : 53|6@0- (0.02,0) [-0.64|0.62] "m"  EOCM_F_FO
 SG_ RSrrTrkRawAzimuth10 : 61|6@0- (1,0) [-32|31] "deg"  EOCM_F_FO

BO_ 1410 RVB_TVR_Debug: 6 EOCM_F_FO
 SG_ VBBrkRqActv : 7|1@0+ (1,0) [0|1] ""  Dummy_FO
 SG_ PATOSTTC : 37|12@0+ (0.025,0) [0|102.375] "s"  Dummy_FO
 SG_ BWTOSObjID : 27|6@0+ (1,0) [0|63] ""  Dummy_FO
 SG_ BWTOSLonPstn : 23|12@0- (0.125,0) [-256|255.875] "m"  Dummy_FO
 SG_ VBSwInd : 10|2@0+ (1,0) [0|3] ""  Dummy_FO
 SG_ VBBrkCtrlSt : 15|3@0+ (1,0) [0|7] ""  Dummy_FO
 SG_ BrkPlsRqst : 6|1@0+ (1,0) [0|1] ""  Dummy_FO
 SG_ VBOpSt : 12|2@0+ (1,0) [0|3] ""  Dummy_FO
 SG_ VBAccelOvrrd : 0|1@0+ (1,0) [0|1] ""  Dummy_FO
 SG_ VBUnavail : 1|1@0+ (1,0) [0|1] ""  Dummy_FO
 SG_ VBFld : 2|1@0+ (1,0) [0|1] ""  Dummy_FO
 SG_ VBDisbld : 3|1@0+ (1,0) [0|1] ""  Dummy_FO
 SG_ VBEnbl : 4|1@0+ (1,0) [0|1] ""  Dummy_FO
 SG_ VBBrkPrfReq : 5|1@0+ (1,0) [0|1] ""  Dummy_FO

BO_ 1216 LF_SRR_Object_Header: 8 LFSRR_FO
 SG_ LFSRRNumValidTargets : 14|4@0+ (1,0) [0|15] ""  EOCM_F_FO
 SG_ LFSrrRollingCnt : 1|2@0+ (1,0) [0|3] ""  EOCM_F_FO
 SG_ LFSRRModeCmdFdbk : 4|3@0+ (1,0) [0|7] ""  EOCM_F_FO
 SG_ LFSrrTimeStampV : 15|1@0+ (1,0) [0|1] ""  EOCM_F_FO
 SG_ LFSrrTimeStamp : 10|11@0+ (1,0) [0|2047] "ms"  EOCM_F_FO
 SG_ LFSrrBurstChecksum : 55|16@0+ (1,0) [0|65535] ""  EOCM_F_FO
 SG_ LFSRRVltgOutRngLo : 44|1@0+ (1,0) [0|1] ""  EOCM_F_FO
 SG_ LFSRRVltgOutRngHi : 43|1@0+ (1,0) [0|1] ""  EOCM_F_FO
 SG_ LFSRRSvcAlgnInPrcs : 38|1@0+ (1,0) [0|1] ""  EOCM_F_FO
 SG_ LFSRRSnsrBlckd : 45|1@0+ (1,0) [0|1] ""  EOCM_F_FO
 SG_ LFSRRSnstvFltPrsntInt : 24|1@0+ (1,0) [0|1] ""  EOCM_F_FO
 SG_ LFSRRPlntAlgnInProc : 37|1@0+ (1,0) [0|1] ""  EOCM_F_FO
 SG_ LFSRRMsalgnYawRt : 47|1@0+ (1,0) [0|1] ""  EOCM_F_FO
 SG_ LFSRRMsalgnYawLt : 46|1@0+ (1,0) [0|1] ""  EOCM_F_FO
 SG_ LFSRRMsalgnRllRt : 35|1@0+ (1,0) [0|1] ""  EOCM_F_FO
 SG_ LFSRRMsalgnRllLt : 34|1@0+ (1,0) [0|1] ""  EOCM_F_FO
 SG_ LFSRRMsalgnPtchUp : 32|1@0+ (1,0) [0|1] ""  EOCM_F_FO
 SG_ LFSRRMsalgnPtchDn : 33|1@0+ (1,0) [0|1] ""  EOCM_F_FO
 SG_ LFSRRInitDiagCmplt : 40|1@0+ (1,0) [0|1] ""  EOCM_F_FO
 SG_ LFSRRHWFltPrsntInt : 25|1@0+ (1,0) [0|1] ""  EOCM_F_FO
 SG_ LFSRRExtIntrfrnc : 36|1@0+ (1,0) [0|1] ""  EOCM_F_FO
 SG_ LFSRRDiagSpare : 30|1@0+ (1,0) [0|1] ""  EOCM_F_FO
 SG_ LFSRRCANSgnlSpvFld : 29|1@0+ (1,0) [0|1] ""  EOCM_F_FO
 SG_ LFSRRCANRxErr : 28|1@0+ (1,0) [0|1] ""  EOCM_F_FO
 SG_ LFSRRCANIDAddrsUnsbl : 27|1@0+ (1,0) [0|1] ""  EOCM_F_FO
 SG_ LFSRRAntTngFltPrsnt : 26|1@0+ (1,0) [0|1] ""  EOCM_F_FO
 SG_ LFSRRAmbTmpOutRngLw : 42|1@0+ (1,0) [0|1] ""  EOCM_F_FO
 SG_ LFSRRAmbTmpOutRngHi : 41|1@0+ (1,0) [0|1] ""  EOCM_F_FO
 SG_ LFSRRAlgnFltPrsnt : 39|1@0+ (1,0) [0|1] ""  EOCM_F_FO

BO_ 1217 LF_SRR_Object_Track1: 8 LFSRR_FO
 SG_ LFSrrBurstID1 : 63|2@0+ (1,0) [0|3] ""  EOCM_F_FO
 SG_ LFSrrTrkRange1 : 2|11@0+ (0.02,0) [0|40.94] "m"  EOCM_F_FO
 SG_ LFSrrTrkRRate1 : 18|11@0- (0.125,0) [-128|127.875] "m/s"  EOCM_F_FO
 SG_ LFSrrTrkAzimuth1 : 34|11@0- (0.125,0) [-128|127.875] "deg"  EOCM_F_FO
 SG_ LFSrrTrkObjID1 : 39|5@0+ (1,0) [0|31] ""  EOCM_F_FO
 SG_ LFSrrTrkObjElevation1 : 20|2@0+ (1,0) [0|3] ""  EOCM_F_FO
 SG_ LFSrrTrkDynamProp1 : 23|3@0+ (1,0) [0|7] ""  EOCM_F_FO
 SG_ LFSrrTrkMeasStatus1 : 55|2@0+ (1,0) [0|3] ""  EOCM_F_FO
 SG_ LFSrrTrkObsRange1 : 53|6@0- (0.02,0) [-0.64|0.62] "m"  EOCM_F_FO
 SG_ LFSrrTrkRawAzimuth1 : 61|6@0- (1,0) [-32|31] "deg"  EOCM_F_FO

BO_ 1218 LF_SRR_Object_Track2: 8 LFSRR_FO
 SG_ LFSrrBurstID2 : 63|2@0+ (1,0) [0|3] ""  EOCM_F_FO
 SG_ LFSrrTrkRange2 : 2|11@0+ (0.02,0) [0|40.94] "m"  EOCM_F_FO
 SG_ LFSrrTrkRRate2 : 18|11@0- (0.125,0) [-128|127.875] "m/s"  EOCM_F_FO
 SG_ LFSrrTrkAzimuth2 : 34|11@0- (0.125,0) [-128|127.875] "deg"  EOCM_F_FO
 SG_ LFSrrTrkObjID2 : 39|5@0+ (1,0) [0|31] ""  EOCM_F_FO
 SG_ LFSrrTrkObjElevation2 : 20|2@0+ (1,0) [0|3] ""  EOCM_F_FO
 SG_ LFSrrTrkDynamProp2 : 23|3@0+ (1,0) [0|7] ""  EOCM_F_FO
 SG_ LFSrrTrkMeasStatus2 : 55|2@0+ (1,0) [0|3] ""  EOCM_F_FO
 SG_ LFSrrTrkObsRange2 : 53|6@0- (0.02,0) [-0.64|0.62] "m"  EOCM_F_FO
 SG_ LFSrrTrkRawAzimuth2 : 61|6@0- (1,0) [-32|31] "deg"  EOCM_F_FO

BO_ 1219 LF_SRR_Object_Track3: 8 LFSRR_FO
 SG_ LFSrrBurstID3 : 63|2@0+ (1,0) [0|3] ""  EOCM_F_FO
 SG_ LFSrrTrkRange3 : 2|11@0+ (0.02,0) [0|40.94] "m"  EOCM_F_FO
 SG_ LFSrrTrkRRate3 : 18|11@0- (0.125,0) [-128|127.875] "m/s"  EOCM_F_FO
 SG_ LFSrrTrkAzimuth3 : 34|11@0- (0.125,0) [-128|127.875] "deg"  EOCM_F_FO
 SG_ LFSrrTrkObjID3 : 39|5@0+ (1,0) [0|31] ""  EOCM_F_FO
 SG_ LFSrrTrkObjElevation3 : 20|2@0+ (1,0) [0|3] ""  EOCM_F_FO
 SG_ LFSrrTrkDynamProp3 : 23|3@0+ (1,0) [0|7] ""  EOCM_F_FO
 SG_ LFSrrTrkMeasStatus3 : 55|2@0+ (1,0) [0|3] ""  EOCM_F_FO
 SG_ LFSrrTrkObsRange3 : 53|6@0- (0.02,0) [-0.64|0.62] "m"  EOCM_F_FO
 SG_ LFSrrTrkRawAzimuth3 : 61|6@0- (1,0) [-32|31] "deg"  EOCM_F_FO

BO_ 1220 LF_SRR_Object_Track4: 8 LFSRR_FO
 SG_ LFSrrBurstID4 : 63|2@0+ (1,0) [0|3] ""  EOCM_F_FO
 SG_ LFSrrTrkRange4 : 2|11@0+ (0.02,0) [0|40.94] "m"  EOCM_F_FO
 SG_ LFSrrTrkRRate4 : 18|11@0- (0.125,0) [-128|127.875] "m/s"  EOCM_F_FO
 SG_ LFSrrTrkObsRange4 : 53|6@0- (0.02,0) [-0.64|0.62] "m"  EOCM_F_FO
 SG_ LFSrrTrkAzimuth4 : 34|11@0- (0.125,0) [-128|127.875] "deg"  EOCM_F_FO
 SG_ LFSrrTrkObjID4 : 39|5@0+ (1,0) [0|31] ""  EOCM_F_FO
 SG_ LFSrrTrkObjElevation4 : 20|2@0+ (1,0) [0|3] ""  EOCM_F_FO
 SG_ LFSrrTrkDynamProp4 : 23|3@0+ (1,0) [0|7] ""  EOCM_F_FO
 SG_ LFSrrTrkMeasStatus4 : 55|2@0+ (1,0) [0|3] ""  EOCM_F_FO
 SG_ LFSrrTrkRawAzimuth4 : 61|6@0- (1,0) [-32|31] "deg"  EOCM_F_FO

BO_ 1221 LF_SRR_Object_Track5: 8 LFSRR_FO
 SG_ LFSrrTrkObsRange5 : 53|6@0- (0.02,0) [-0.64|0.62] "m"  EOCM_F_FO
 SG_ LFSrrBurstID5 : 63|2@0+ (1,0) [0|3] ""  EOCM_F_FO
 SG_ LFSrrTrkRange5 : 2|11@0+ (0.02,0) [0|40.94] "m"  EOCM_F_FO
 SG_ LFSrrTrkRRate5 : 18|11@0- (0.125,0) [-128|127.875] "m/s"  EOCM_F_FO
 SG_ LFSrrTrkAzimuth5 : 34|11@0- (0.125,0) [-128|127.875] "deg"  EOCM_F_FO
 SG_ LFSrrTrkObjID5 : 39|5@0+ (1,0) [0|31] ""  EOCM_F_FO
 SG_ LFSrrTrkObjElevation5 : 20|2@0+ (1,0) [0|3] ""  EOCM_F_FO
 SG_ LFSrrTrkDynamProp5 : 23|3@0+ (1,0) [0|7] ""  EOCM_F_FO
 SG_ LFSrrTrkMeasStatus5 : 55|2@0+ (1,0) [0|3] ""  EOCM_F_FO
 SG_ LFSrrTrkRawAzimuth5 : 61|6@0- (1,0) [-32|31] "deg"  EOCM_F_FO

BO_ 1222 LF_SRR_Object_Track6: 8 LFSRR_FO
 SG_ LFSrrTrkObsRange6 : 53|6@0- (0.02,0) [-0.64|0.62] "m"  EOCM_F_FO
 SG_ LFSrrBurstID6 : 63|2@0+ (1,0) [0|3] ""  EOCM_F_FO
 SG_ LFSrrTrkRange6 : 2|11@0+ (0.02,0) [0|40.94] "m"  EOCM_F_FO
 SG_ LFSrrTrkRRate6 : 18|11@0- (0.125,0) [-128|127.875] "m/s"  EOCM_F_FO
 SG_ LFSrrTrkAzimuth6 : 34|11@0- (0.125,0) [-128|127.875] "deg"  EOCM_F_FO
 SG_ LFSrrTrkObjID6 : 39|5@0+ (1,0) [0|31] ""  EOCM_F_FO
 SG_ LFSrrTrkObjElevation6 : 20|2@0+ (1,0) [0|3] ""  EOCM_F_FO
 SG_ LFSrrTrkDynamProp6 : 23|3@0+ (1,0) [0|7] ""  EOCM_F_FO
 SG_ LFSrrTrkMeasStatus6 : 55|2@0+ (1,0) [0|3] ""  EOCM_F_FO
 SG_ LFSrrTrkRawAzimuth6 : 61|6@0- (1,0) [-32|31] "deg"  EOCM_F_FO

BO_ 1223 LF_SRR_Object_Track7: 8 LFSRR_FO
 SG_ LFSrrTrkObsRange7 : 53|6@0- (0.02,0) [-0.64|0.62] "m"  EOCM_F_FO
 SG_ LFSrrBurstID7 : 63|2@0+ (1,0) [0|3] ""  EOCM_F_FO
 SG_ LFSrrTrkRange7 : 2|11@0+ (0.02,0) [0|40.94] "m"  EOCM_F_FO
 SG_ LFSrrTrkRRate7 : 18|11@0- (0.125,0) [-128|127.875] "m/s"  EOCM_F_FO
 SG_ LFSrrTrkAzimuth7 : 34|11@0- (0.125,0) [-128|127.875] "deg"  EOCM_F_FO
 SG_ LFSrrTrkObjID7 : 39|5@0+ (1,0) [0|31] ""  EOCM_F_FO
 SG_ LFSrrTrkObjElevation7 : 20|2@0+ (1,0) [0|3] ""  EOCM_F_FO
 SG_ LFSrrTrkDynamProp7 : 23|3@0+ (1,0) [0|7] ""  EOCM_F_FO
 SG_ LFSrrTrkMeasStatus7 : 55|2@0+ (1,0) [0|3] ""  EOCM_F_FO
 SG_ LFSrrTrkRawAzimuth7 : 61|6@0- (1,0) [-32|31] "deg"  EOCM_F_FO

BO_ 1224 LF_SRR_Object_Track8: 8 LFSRR_FO
 SG_ LFSrrTrkObsRange8 : 53|6@0- (0.02,0) [-0.64|0.62] "m"  EOCM_F_FO
 SG_ LFSrrBurstID8 : 63|2@0+ (1,0) [0|3] ""  EOCM_F_FO
 SG_ LFSrrTrkRange8 : 2|11@0+ (0.02,0) [0|40.94] "m"  EOCM_F_FO
 SG_ LFSrrTrkRRate8 : 18|11@0- (0.125,0) [-128|127.875] "m/s"  EOCM_F_FO
 SG_ LFSrrTrkAzimuth8 : 34|11@0- (0.125,0) [-128|127.875] "deg"  EOCM_F_FO
 SG_ LFSrrTrkObjID8 : 39|5@0+ (1,0) [0|31] ""  EOCM_F_FO
 SG_ LFSrrTrkObjElevation8 : 20|2@0+ (1,0) [0|3] ""  EOCM_F_FO
 SG_ LFSrrTrkDynamProp8 : 23|3@0+ (1,0) [0|7] ""  EOCM_F_FO
 SG_ LFSrrTrkMeasStatus8 : 55|2@0+ (1,0) [0|3] ""  EOCM_F_FO
 SG_ LFSrrTrkRawAzimuth8 : 61|6@0- (1,0) [-32|31] "deg"  EOCM_F_FO

BO_ 1225 LF_SRR_Object_Track9: 8 LFSRR_FO
 SG_ LFSrrTrkObsRange9 : 53|6@0- (0.02,0) [-0.64|0.62] "m"  EOCM_F_FO
 SG_ LFSrrBurstID9 : 63|2@0+ (1,0) [0|3] ""  EOCM_F_FO
 SG_ LFSrrTrkRange9 : 2|11@0+ (0.02,0) [0|40.94] "m"  EOCM_F_FO
 SG_ LFSrrTrkRRate9 : 18|11@0- (0.125,0) [-128|127.875] "m/s"  EOCM_F_FO
 SG_ LFSrrTrkAzimuth9 : 34|11@0- (0.125,0) [-128|127.875] "deg"  EOCM_F_FO
 SG_ LFSrrTrkObjID9 : 39|5@0+ (1,0) [0|31] ""  EOCM_F_FO
 SG_ LFSrrTrkObjElevation9 : 20|2@0+ (1,0) [0|3] ""  EOCM_F_FO
 SG_ LFSrrTrkDynamProp9 : 23|3@0+ (1,0) [0|7] ""  EOCM_F_FO
 SG_ LFSrrTrkMeasStatus9 : 55|2@0+ (1,0) [0|3] ""  EOCM_F_FO
 SG_ LFSrrTrkRawAzimuth9 : 61|6@0- (1,0) [-32|31] "deg"  EOCM_F_FO

BO_ 1226 LF_SRR_Object_Track10: 8 LFSRR_FO
 SG_ LFSrrTrkObsRange10 : 53|6@0- (0.02,0) [-0.64|0.62] "m"  EOCM_F_FO
 SG_ LFSrrBurstID10 : 63|2@0+ (1,0) [0|3] ""  EOCM_F_FO
 SG_ LFSrrTrkRange10 : 2|11@0+ (0.02,0) [0|40.94] "m"  EOCM_F_FO
 SG_ LFSrrTrkRRate10 : 18|11@0- (0.125,0) [-128|127.875] "m/s"  EOCM_F_FO
 SG_ LFSrrTrkAzimuth10 : 34|11@0- (0.125,0) [-128|127.875] "deg"  EOCM_F_FO
 SG_ LFSrrTrkObjID10 : 39|5@0+ (1,0) [0|31] ""  EOCM_F_FO
 SG_ LFSrrTrkObjElevation10 : 20|2@0+ (1,0) [0|3] ""  EOCM_F_FO
 SG_ LFSrrTrkDynamProp10 : 23|3@0+ (1,0) [0|7] ""  EOCM_F_FO
 SG_ LFSrrTrkMeasStatus10 : 55|2@0+ (1,0) [0|3] ""  EOCM_F_FO
 SG_ LFSrrTrkRawAzimuth10 : 61|6@0- (1,0) [-32|31] "deg"  EOCM_F_FO

BO_ 1232 RF_SRR_Object_Header: 8 RFSRR_FO
 SG_ RFSRRVltgOutRngLo : 44|1@0+ (1,0) [0|1] ""  EOCM_F_FO
 SG_ RFSRRVltgOutRngHi : 43|1@0+ (1,0) [0|1] ""  EOCM_F_FO
 SG_ RFSRRSvcAlgnInPrcs : 38|1@0+ (1,0) [0|1] ""  EOCM_F_FO
 SG_ RFSRRSnsrBlckd : 45|1@0+ (1,0) [0|1] ""  EOCM_F_FO
 SG_ RFSRRSnstvFltPrsntInt : 24|1@0+ (1,0) [0|1] ""  EOCM_F_FO
 SG_ RFSRRPlntAlgnInProc : 37|1@0+ (1,0) [0|1] ""  EOCM_F_FO
 SG_ RFSRRMsalgnYawRt : 47|1@0+ (1,0) [0|1] ""  EOCM_F_FO
 SG_ RFSRRMsalgnYawLt : 46|1@0+ (1,0) [0|1] ""  EOCM_F_FO
 SG_ RFSRRMsalgnRllRt : 35|1@0+ (1,0) [0|1] ""  EOCM_F_FO
 SG_ RFSRRMsalgnRllLt : 34|1@0+ (1,0) [0|1] ""  EOCM_F_FO
 SG_ RFSRRMsalgnPtchUp : 32|1@0+ (1,0) [0|1] ""  EOCM_F_FO
 SG_ RFSRRMsalgnPtchDn : 33|1@0+ (1,0) [0|1] ""  EOCM_F_FO
 SG_ RFSRRInitDiagCmplt : 40|1@0+ (1,0) [0|1] ""  EOCM_F_FO
 SG_ RFSRRHWFltPrsntInt : 25|1@0+ (1,0) [0|1] ""  EOCM_F_FO
 SG_ RFSRRExtIntrfrnc : 36|1@0+ (1,0) [0|1] ""  EOCM_F_FO
 SG_ RFSRRDiagSpare : 30|1@0+ (1,0) [0|1] ""  EOCM_F_FO
 SG_ RFSRRCANSgnlSpvFld : 29|1@0+ (1,0) [0|1] ""  EOCM_F_FO
 SG_ RFSRRCANRxErr : 28|1@0+ (1,0) [0|1] ""  EOCM_F_FO
 SG_ RFSRRCANIDAddrsUnsbl : 27|1@0+ (1,0) [0|1] ""  EOCM_F_FO
 SG_ RFSRRAntTngFltPrsnt : 26|1@0+ (1,0) [0|1] ""  EOCM_F_FO
 SG_ RFSRRAmbTmpOutRngLw : 42|1@0+ (1,0) [0|1] ""  EOCM_F_FO
 SG_ RFSRRAmbTmpOutRngHi : 41|1@0+ (1,0) [0|1] ""  EOCM_F_FO
 SG_ RFSRRAlgnFltPrsnt : 39|1@0+ (1,0) [0|1] ""  EOCM_F_FO
 SG_ RFSRRNumValidTargets : 14|4@0+ (1,0) [0|15] ""  EOCM_F_FO
 SG_ RFSrrRollingCnt : 1|2@0+ (1,0) [0|3] ""  EOCM_F_FO
 SG_ RFSRRModeCmdFdbk : 4|3@0+ (1,0) [0|7] ""  EOCM_F_FO
 SG_ RFSrrTimeStamp : 10|11@0+ (1,0) [0|2047] "ms"  EOCM_F_FO
 SG_ RFSrrBurstChecksum : 55|16@0+ (1,0) [0|65535] ""  EOCM_F_FO
 SG_ RFSrrTimeStampV : 15|1@0+ (1,0) [0|1] ""  EOCM_F_FO

BO_ 1233 RF_SRR_Object_Track1: 8 RFSRR_FO
 SG_ RFSrrTrkObsRange1 : 53|6@0- (0.02,0) [-0.64|0.62] "m"  EOCM_F_FO
 SG_ RFSrrTrkRawAzimuth1 : 61|6@0- (1,0) [-32|31] "deg"  EOCM_F_FO
 SG_ RFSrrBurstID1 : 63|2@0+ (1,0) [0|3] ""  EOCM_F_FO
 SG_ RFSrrTrkRange1 : 2|11@0+ (0.02,0) [0|40.94] "m"  EOCM_F_FO
 SG_ RFSrrTrkRRate1 : 18|11@0- (0.125,0) [-128|127.875] "m/s"  EOCM_F_FO
 SG_ RFSrrTrkAzimuth1 : 34|11@0- (0.125,0) [-128|127.875] "deg"  EOCM_F_FO
 SG_ RFSrrTrkObjID1 : 39|5@0+ (1,0) [0|31] ""  EOCM_F_FO
 SG_ RFSrrTrkObjElevation1 : 20|2@0+ (1,0) [0|3] ""  EOCM_F_FO
 SG_ RFSrrTrkDynamProp1 : 23|3@0+ (1,0) [0|7] ""  EOCM_F_FO
 SG_ RFSrrTrkMeasStatus1 : 55|2@0+ (1,0) [0|3] ""  EOCM_F_FO

BO_ 1234 RF_SRR_Object_Track2: 8 RFSRR_FO
 SG_ RFSrrTrkObsRange2 : 53|6@0- (0.02,0) [-0.64|0.62] "m"  EOCM_F_FO
 SG_ RFSrrTrkRawAzimuth2 : 61|6@0- (1,0) [-32|31] "deg"  EOCM_F_FO
 SG_ RFSrrBurstID2 : 63|2@0+ (1,0) [0|3] ""  EOCM_F_FO
 SG_ RFSrrTrkRange2 : 2|11@0+ (0.02,0) [0|40.94] "m"  EOCM_F_FO
 SG_ RFSrrTrkRRate2 : 18|11@0- (0.125,0) [-128|127.875] "m/s"  EOCM_F_FO
 SG_ RFSrrTrkAzimuth2 : 34|11@0- (0.125,0) [-128|127.875] "deg"  EOCM_F_FO
 SG_ RFSrrTrkObjID2 : 39|5@0+ (1,0) [0|31] ""  EOCM_F_FO
 SG_ RFSrrTrkObjElevation2 : 20|2@0+ (1,0) [0|3] ""  EOCM_F_FO
 SG_ RFSrrTrkDynamProp2 : 23|3@0+ (1,0) [0|7] ""  EOCM_F_FO
 SG_ RFSrrTrkMeasStatus2 : 55|2@0+ (1,0) [0|3] ""  EOCM_F_FO

BO_ 1235 RF_SRR_Object_Track3: 8 RFSRR_FO
 SG_ RFSrrTrkObsRange3 : 53|6@0- (0.02,0) [-0.64|0.62] "m"  EOCM_F_FO
 SG_ RFSrrTrkRawAzimuth3 : 61|6@0- (1,0) [-32|31] "deg"  EOCM_F_FO
 SG_ RFSrrBurstID3 : 63|2@0+ (1,0) [0|3] ""  EOCM_F_FO
 SG_ RFSrrTrkRange3 : 2|11@0+ (0.02,0) [0|40.94] "m"  EOCM_F_FO
 SG_ RFSrrTrkRRate3 : 18|11@0- (0.125,0) [-128|127.875] "m/s"  EOCM_F_FO
 SG_ RFSrrTrkAzimuth3 : 34|11@0- (0.125,0) [-128|127.875] "deg"  EOCM_F_FO
 SG_ RFSrrTrkObjID3 : 39|5@0+ (1,0) [0|31] ""  EOCM_F_FO
 SG_ RFSrrTrkObjElevation3 : 20|2@0+ (1,0) [0|3] ""  EOCM_F_FO
 SG_ RFSrrTrkDynamProp3 : 23|3@0+ (1,0) [0|7] ""  EOCM_F_FO
 SG_ RFSrrTrkMeasStatus3 : 55|2@0+ (1,0) [0|3] ""  EOCM_F_FO

BO_ 1236 RF_SRR_Object_Track4: 8 RFSRR_FO
 SG_ RFSrrTrkObsRange4 : 53|6@0- (0.02,0) [-0.64|0.62] "m"  EOCM_F_FO
 SG_ RFSrrTrkRawAzimuth4 : 61|6@0- (1,0) [-32|31] "deg"  EOCM_F_FO
 SG_ RFSrrBurstID4 : 63|2@0+ (1,0) [0|3] ""  EOCM_F_FO
 SG_ RFSrrTrkRange4 : 2|11@0+ (0.02,0) [0|40.94] "m"  EOCM_F_FO
 SG_ RFSrrTrkRRate4 : 18|11@0- (0.125,0) [-128|127.875] "m/s"  EOCM_F_FO
 SG_ RFSrrTrkAzimuth4 : 34|11@0- (0.125,0) [-128|127.875] "deg"  EOCM_F_FO
 SG_ RFSrrTrkObjID4 : 39|5@0+ (1,0) [0|31] ""  EOCM_F_FO
 SG_ RFSrrTrkObjElevation4 : 20|2@0+ (1,0) [0|3] ""  EOCM_F_FO
 SG_ RFSrrTrkDynamProp4 : 23|3@0+ (1,0) [0|7] ""  EOCM_F_FO
 SG_ RFSrrTrkMeasStatus4 : 55|2@0+ (1,0) [0|3] ""  EOCM_F_FO

BO_ 1237 RF_SRR_Object_Track5: 8 RFSRR_FO
 SG_ RFSrrTrkObsRange5 : 53|6@0- (0.02,0) [-0.64|0.62] "m"  EOCM_F_FO
 SG_ RFSrrTrkRawAzimuth5 : 61|6@0- (1,0) [-32|31] "deg"  EOCM_F_FO
 SG_ RFSrrBurstID5 : 63|2@0+ (1,0) [0|3] ""  EOCM_F_FO
 SG_ RFSrrTrkRange5 : 2|11@0+ (0.02,0) [0|40.94] "m"  EOCM_F_FO
 SG_ RFSrrTrkRRate5 : 18|11@0- (0.125,0) [-128|127.875] "m/s"  EOCM_F_FO
 SG_ RFSrrTrkAzimuth5 : 34|11@0- (0.125,0) [-128|127.875] "deg"  EOCM_F_FO
 SG_ RFSrrTrkObjID5 : 39|5@0+ (1,0) [0|31] ""  EOCM_F_FO
 SG_ RFSrrTrkObjElevation5 : 20|2@0+ (1,0) [0|3] ""  EOCM_F_FO
 SG_ RFSrrTrkDynamProp5 : 23|3@0+ (1,0) [0|7] ""  EOCM_F_FO
 SG_ RFSrrTrkMeasStatus5 : 55|2@0+ (1,0) [0|3] ""  EOCM_F_FO

BO_ 1238 RF_SRR_Object_Track6: 8 RFSRR_FO
 SG_ RFSrrTrkObsRange6 : 53|6@0- (0.02,0) [-0.64|0.62] "m"  EOCM_F_FO
 SG_ RFSrrTrkRawAzimuth6 : 61|6@0- (1,0) [-32|31] "deg"  EOCM_F_FO
 SG_ RFSrrBurstID6 : 63|2@0+ (1,0) [0|3] ""  EOCM_F_FO
 SG_ RFSrrTrkRange6 : 2|11@0+ (0.02,0) [0|40.94] "m"  EOCM_F_FO
 SG_ RFSrrTrkRRate6 : 18|11@0- (0.125,0) [-128|127.875] "m/s"  EOCM_F_FO
 SG_ RFSrrTrkAzimuth6 : 34|11@0- (0.125,0) [-128|127.875] "deg"  EOCM_F_FO
 SG_ RFSrrTrkObjID6 : 39|5@0+ (1,0) [0|31] ""  EOCM_F_FO
 SG_ RFSrrTrkObjElevation6 : 20|2@0+ (1,0) [0|3] ""  EOCM_F_FO
 SG_ RFSrrTrkDynamProp6 : 23|3@0+ (1,0) [0|7] ""  EOCM_F_FO
 SG_ RFSrrTrkMeasStatus6 : 55|2@0+ (1,0) [0|3] ""  EOCM_F_FO

BO_ 1239 RF_SRR_Object_Track7: 8 RFSRR_FO
 SG_ RFSrrTrkObsRange7 : 53|6@0- (0.02,0) [-0.64|0.62] "m"  EOCM_F_FO
 SG_ RFSrrTrkRawAzimuth7 : 61|6@0- (1,0) [-32|31] "deg"  EOCM_F_FO
 SG_ RFSrrBurstID7 : 63|2@0+ (1,0) [0|3] ""  EOCM_F_FO
 SG_ RFSrrTrkRange7 : 2|11@0+ (0.02,0) [0|40.94] "m"  EOCM_F_FO
 SG_ RFSrrTrkRRate7 : 18|11@0- (0.125,0) [-128|127.875] "m/s"  EOCM_F_FO
 SG_ RFSrrTrkAzimuth7 : 34|11@0- (0.125,0) [-128|127.875] "deg"  EOCM_F_FO
 SG_ RFSrrTrkObjID7 : 39|5@0+ (1,0) [0|31] ""  EOCM_F_FO
 SG_ RFSrrTrkObjElevation7 : 20|2@0+ (1,0) [0|3] ""  EOCM_F_FO
 SG_ RFSrrTrkDynamProp7 : 23|3@0+ (1,0) [0|7] ""  EOCM_F_FO
 SG_ RFSrrTrkMeasStatus7 : 55|2@0+ (1,0) [0|3] ""  EOCM_F_FO

BO_ 1240 RF_SRR_Object_Track8: 8 RFSRR_FO
 SG_ RFSrrTrkObsRange8 : 53|6@0- (0.02,0) [-0.64|0.62] "m"  EOCM_F_FO
 SG_ RFSrrTrkRawAzimuth8 : 61|6@0- (1,0) [-32|31] "deg"  EOCM_F_FO
 SG_ RFSrrBurstID8 : 63|2@0+ (1,0) [0|3] ""  EOCM_F_FO
 SG_ RFSrrTrkRange8 : 2|11@0+ (0.02,0) [0|40.94] "m"  EOCM_F_FO
 SG_ RFSrrTrkRRate8 : 18|11@0- (0.125,0) [-128|127.875] "m/s"  EOCM_F_FO
 SG_ RFSrrTrkAzimuth8 : 34|11@0- (0.125,0) [-128|127.875] "deg"  EOCM_F_FO
 SG_ RFSrrTrkObjID8 : 39|5@0+ (1,0) [0|31] ""  EOCM_F_FO
 SG_ RFSrrTrkObjElevation8 : 20|2@0+ (1,0) [0|3] ""  EOCM_F_FO
 SG_ RFSrrTrkDynamProp8 : 23|3@0+ (1,0) [0|7] ""  EOCM_F_FO
 SG_ RFSrrTrkMeasStatus8 : 55|2@0+ (1,0) [0|3] ""  EOCM_F_FO

BO_ 1241 RF_SRR_Object_Track9: 8 RFSRR_FO
 SG_ RFSrrTrkObsRange9 : 53|6@0- (0.02,0) [-0.64|0.62] "m"  EOCM_F_FO
 SG_ RFSrrTrkRawAzimuth9 : 61|6@0- (1,0) [-32|31] "deg"  EOCM_F_FO
 SG_ RFSrrBurstID9 : 63|2@0+ (1,0) [0|3] ""  EOCM_F_FO
 SG_ RFSrrTrkRange9 : 2|11@0+ (0.02,0) [0|40.94] "m"  EOCM_F_FO
 SG_ RFSrrTrkRRate9 : 18|11@0- (0.125,0) [-128|127.875] "m/s"  EOCM_F_FO
 SG_ RFSrrTrkAzimuth9 : 34|11@0- (0.125,0) [-128|127.875] "deg"  EOCM_F_FO
 SG_ RFSrrTrkObjID9 : 39|5@0+ (1,0) [0|31] ""  EOCM_F_FO
 SG_ RFSrrTrkObjElevation9 : 20|2@0+ (1,0) [0|3] ""  EOCM_F_FO
 SG_ RFSrrTrkDynamProp9 : 23|3@0+ (1,0) [0|7] ""  EOCM_F_FO
 SG_ RFSrrTrkMeasStatus9 : 55|2@0+ (1,0) [0|3] ""  EOCM_F_FO

BO_ 1242 RF_SRR_Object_Track10: 8 RFSRR_FO
 SG_ RFSrrTrkObsRange10 : 53|6@0- (0.02,0) [-0.64|0.62] "m"  EOCM_F_FO
 SG_ RFSrrTrkRawAzimuth10 : 61|6@0- (1,0) [-32|31] "deg"  EOCM_F_FO
 SG_ RFSrrBurstID10 : 63|2@0+ (1,0) [0|3] ""  EOCM_F_FO
 SG_ RFSrrTrkRange10 : 2|11@0+ (0.02,0) [0|40.94] "m"  EOCM_F_FO
 SG_ RFSrrTrkRRate10 : 18|11@0- (0.125,0) [-128|127.875] "m/s"  EOCM_F_FO
 SG_ RFSrrTrkAzimuth10 : 34|11@0- (0.125,0) [-128|127.875] "deg"  EOCM_F_FO
 SG_ RFSrrTrkObjID10 : 39|5@0+ (1,0) [0|31] ""  EOCM_F_FO
 SG_ RFSrrTrkObjElevation10 : 20|2@0+ (1,0) [0|3] ""  EOCM_F_FO
 SG_ RFSrrTrkDynamProp10 : 23|3@0+ (1,0) [0|7] ""  EOCM_F_FO
 SG_ RFSrrTrkMeasStatus10 : 55|2@0+ (1,0) [0|3] ""  EOCM_F_FO

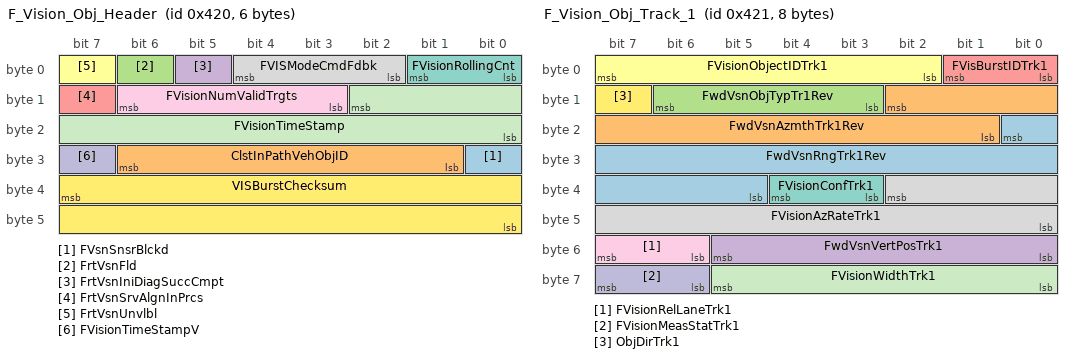
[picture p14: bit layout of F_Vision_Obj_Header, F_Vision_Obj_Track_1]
BO_ 1056 F_Vision_Obj_Header: 6 VIS_FO
 SG_ FVsnSnsrBlckd : 24|1@0+ (1,0) [0|1] ""  EOCM_F_FO
 SG_ ClstInPathVehObjID : 30|6@0+ (1,0) [0|63] ""  EOCM_F_FO
 SG_ FrtVsnFld : 6|1@0+ (1,0) [0|1] ""  EOCM_F_FO
 SG_ FrtVsnIniDiagSuccCmpt : 5|1@0+ (1,0) [0|1] ""  EOCM_F_FO
 SG_ FrtVsnSrvAlgnInPrcs : 15|1@0+ (1,0) [0|1] ""  EOCM_F_FO
 SG_ FrtVsnUnvlbl : 7|1@0+ (1,0) [0|1] ""  EOCM_F_FO
 SG_ FVisionRollingCnt : 1|2@0+ (1,0) [0|3] ""  EOCM_F_FO
 SG_ FVISModeCmdFdbk : 4|3@0+ (1,0) [0|7] ""  EOCM_F_FO
 SG_ FVisionNumValidTrgts : 14|4@0+ (1,0) [0|15] ""  EOCM_F_FO
 SG_ FVisionTimeStampV : 31|1@0+ (1,0) [0|1] ""  EOCM_F_FO
 SG_ FVisionTimeStamp : 10|11@0+ (1,0) [0|2047] "ms"  EOCM_F_FO
 SG_ VISBurstChecksum : 39|16@0+ (1,0) [0|65535] ""  EOCM_F_FO

BO_ 1057 F_Vision_Obj_Track_1: 8 VIS_FO
 SG_ FwdVsnRngTrk1Rev : 16|12@0+ (0.1,0) [0|409.5] "m"  EOCM_F_FO
 SG_ FwdVsnAzmthTrk1Rev : 10|10@0- (0.1,0) [-51.2|51.1] "deg"  EOCM_F_FO
 SG_ FwdVsnObjTypTr1Rev : 14|4@0+ (1,0) [0|15] ""  EOCM_F_FO
 SG_ FwdVsnVertPosTrk1 : 53|6@0+ (0.25,-2) [-2|13.75] "deg"  EOCM_F_FO
 SG_ FVisBurstIDTrk1 : 1|2@0+ (1,0) [0|3] ""  EOCM_F_FO
 SG_ FVisionObjectIDTrk1 : 7|6@0+ (1,0) [0|63] ""  EOCM_F_FO
 SG_ FVisionConfTrk1 : 36|2@0+ (1,0) [0|3] ""  EOCM_F_FO
 SG_ FVisionAzRateTrk1 : 34|11@0- (0.125,0) [-128|127.875] "deg/s"  EOCM_F_FO
 SG_ FVisionRelLaneTrk1 : 55|2@0+ (1,0) [0|3] ""  EOCM_F_FO
 SG_ FVisionMeasStatTrk1 : 63|2@0+ (1,0) [0|3] ""  EOCM_F_FO
 SG_ FVisionWidthTrk1 : 61|6@0+ (0.25,0) [0|15.75] "m"  EOCM_F_FO
 SG_ ObjDirTrk1 : 15|1@0+ (1,0) [0|1] ""  EOCM_F_FO

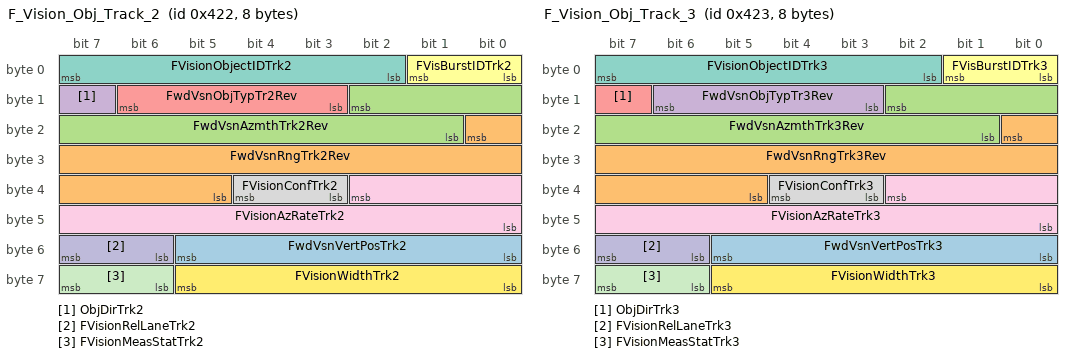
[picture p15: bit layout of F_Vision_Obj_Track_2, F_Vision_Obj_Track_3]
BO_ 1058 F_Vision_Obj_Track_2: 8 VIS_FO
 SG_ FwdVsnVertPosTrk2 : 53|6@0+ (0.25,-2) [-2|13.75] "deg"  EOCM_F_FO
 SG_ FwdVsnRngTrk2Rev : 16|12@0+ (0.1,0) [0|409.5] "m"  EOCM_F_FO
 SG_ FwdVsnAzmthTrk2Rev : 10|10@0- (0.1,0) [-51.2|51.1] "deg"  EOCM_F_FO
 SG_ ObjDirTrk2 : 15|1@0+ (1,0) [0|1] ""  EOCM_F_FO
 SG_ FwdVsnObjTypTr2Rev : 14|4@0+ (1,0) [0|15] ""  EOCM_F_FO
 SG_ FVisBurstIDTrk2 : 1|2@0+ (1,0) [0|3] ""  EOCM_F_FO
 SG_ FVisionObjectIDTrk2 : 7|6@0+ (1,0) [0|63] ""  EOCM_F_FO
 SG_ FVisionConfTrk2 : 36|2@0+ (1,0) [0|3] ""  EOCM_F_FO
 SG_ FVisionAzRateTrk2 : 34|11@0- (0.125,0) [-128|127.875] "deg/s"  EOCM_F_FO
 SG_ FVisionRelLaneTrk2 : 55|2@0+ (1,0) [0|3] ""  EOCM_F_FO
 SG_ FVisionMeasStatTrk2 : 63|2@0+ (1,0) [0|3] ""  EOCM_F_FO
 SG_ FVisionWidthTrk2 : 61|6@0+ (0.25,0) [0|15.75] "m"  EOCM_F_FO

BO_ 1059 F_Vision_Obj_Track_3: 8 VIS_FO
 SG_ FwdVsnVertPosTrk3 : 53|6@0+ (0.25,-2) [-2|13.75] "deg"  EOCM_F_FO
 SG_ FwdVsnRngTrk3Rev : 16|12@0+ (0.1,0) [0|409.5] "m"  EOCM_F_FO
 SG_ FwdVsnAzmthTrk3Rev : 10|10@0- (0.1,0) [-51.2|51.1] "deg"  EOCM_F_FO
 SG_ FwdVsnObjTypTr3Rev : 14|4@0+ (1,0) [0|15] ""  EOCM_F_FO
 SG_ ObjDirTrk3 : 15|1@0+ (1,0) [0|1] ""  EOCM_F_FO
 SG_ FVisBurstIDTrk3 : 1|2@0+ (1,0) [0|3] ""  EOCM_F_FO
 SG_ FVisionObjectIDTrk3 : 7|6@0+ (1,0) [0|63] ""  EOCM_F_FO
 SG_ FVisionConfTrk3 : 36|2@0+ (1,0) [0|3] ""  EOCM_F_FO
 SG_ FVisionAzRateTrk3 : 34|11@0- (0.125,0) [-128|127.875] "deg/s"  EOCM_F_FO
 SG_ FVisionRelLaneTrk3 : 55|2@0+ (1,0) [0|3] ""  EOCM_F_FO
 SG_ FVisionMeasStatTrk3 : 63|2@0+ (1,0) [0|3] ""  EOCM_F_FO
 SG_ FVisionWidthTrk3 : 61|6@0+ (0.25,0) [0|15.75] "m"  EOCM_F_FO

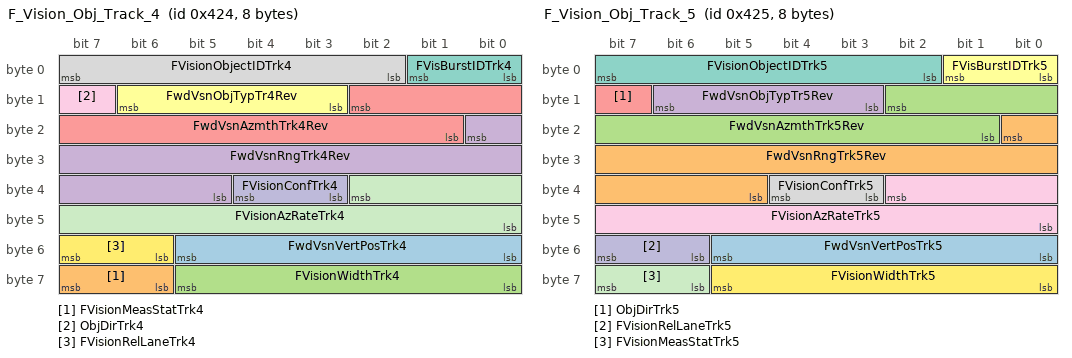
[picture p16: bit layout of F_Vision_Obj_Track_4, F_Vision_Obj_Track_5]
BO_ 1060 F_Vision_Obj_Track_4: 8 VIS_FO
 SG_ FwdVsnVertPosTrk4 : 53|6@0+ (0.25,-2) [-2|13.75] "deg"  EOCM_F_FO
 SG_ FVisionMeasStatTrk4 : 63|2@0+ (1,0) [0|3] ""  EOCM_F_FO
 SG_ FVisionWidthTrk4 : 61|6@0+ (0.25,0) [0|15.75] "m"  EOCM_F_FO
 SG_ FwdVsnRngTrk4Rev : 16|12@0+ (0.1,0) [0|409.5] "m"  EOCM_F_FO
 SG_ FwdVsnAzmthTrk4Rev : 10|10@0- (0.1,0) [-51.2|51.1] "deg"  EOCM_F_FO
 SG_ FwdVsnObjTypTr4Rev : 14|4@0+ (1,0) [0|15] ""  EOCM_F_FO
 SG_ FVisBurstIDTrk4 : 1|2@0+ (1,0) [0|3] ""  EOCM_F_FO
 SG_ FVisionObjectIDTrk4 : 7|6@0+ (1,0) [0|63] ""  EOCM_F_FO
 SG_ ObjDirTrk4 : 15|1@0+ (1,0) [0|1] ""  EOCM_F_FO
 SG_ FVisionConfTrk4 : 36|2@0+ (1,0) [0|3] ""  EOCM_F_FO
 SG_ FVisionAzRateTrk4 : 34|11@0- (0.125,0) [-128|127.875] "deg/s"  EOCM_F_FO
 SG_ FVisionRelLaneTrk4 : 55|2@0+ (1,0) [0|3] ""  EOCM_F_FO

BO_ 1061 F_Vision_Obj_Track_5: 8 VIS_FO
 SG_ FwdVsnVertPosTrk5 : 53|6@0+ (0.25,-2) [-2|13.75] "deg"  EOCM_F_FO
 SG_ FwdVsnRngTrk5Rev : 16|12@0+ (0.1,0) [0|409.5] "m"  EOCM_F_FO
 SG_ FwdVsnAzmthTrk5Rev : 10|10@0- (0.1,0) [-51.2|51.1] "deg"  EOCM_F_FO
 SG_ FwdVsnObjTypTr5Rev : 14|4@0+ (1,0) [0|15] ""  EOCM_F_FO
 SG_ ObjDirTrk5 : 15|1@0+ (1,0) [0|1] ""  EOCM_F_FO
 SG_ FVisBurstIDTrk5 : 1|2@0+ (1,0) [0|3] ""  EOCM_F_FO
 SG_ FVisionObjectIDTrk5 : 7|6@0+ (1,0) [0|63] ""  EOCM_F_FO
 SG_ FVisionConfTrk5 : 36|2@0+ (1,0) [0|3] ""  EOCM_F_FO
 SG_ FVisionAzRateTrk5 : 34|11@0- (0.125,0) [-128|127.875] "deg/s"  EOCM_F_FO
 SG_ FVisionRelLaneTrk5 : 55|2@0+ (1,0) [0|3] ""  EOCM_F_FO
 SG_ FVisionMeasStatTrk5 : 63|2@0+ (1,0) [0|3] ""  EOCM_F_FO
 SG_ FVisionWidthTrk5 : 61|6@0+ (0.25,0) [0|15.75] "m"  EOCM_F_FO

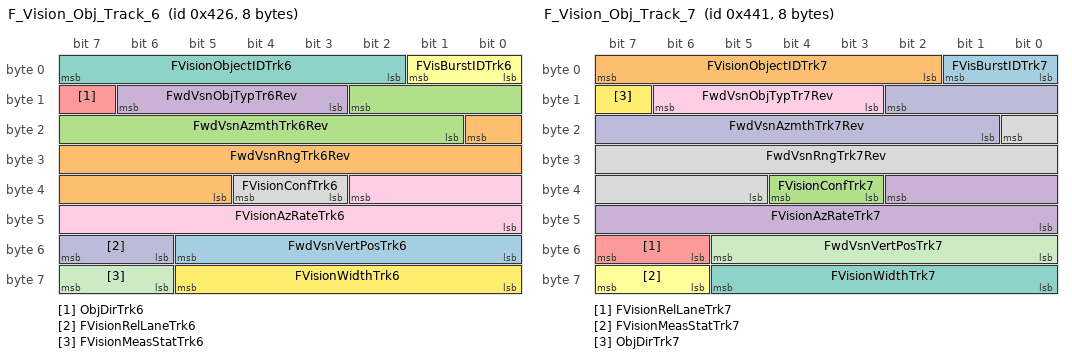
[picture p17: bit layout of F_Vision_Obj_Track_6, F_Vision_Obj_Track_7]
BO_ 1062 F_Vision_Obj_Track_6: 8 VIS_FO
 SG_ FwdVsnVertPosTrk6 : 53|6@0+ (0.25,-2) [-2|13.75] "deg"  EOCM_F_FO
 SG_ FwdVsnRngTrk6Rev : 16|12@0+ (0.1,0) [0|409.5] "m"  EOCM_F_FO
 SG_ FwdVsnAzmthTrk6Rev : 10|10@0- (0.1,0) [-51.2|51.1] "deg"  EOCM_F_FO
 SG_ FwdVsnObjTypTr6Rev : 14|4@0+ (1,0) [0|15] ""  EOCM_F_FO
 SG_ ObjDirTrk6 : 15|1@0+ (1,0) [0|1] ""  EOCM_F_FO
 SG_ FVisBurstIDTrk6 : 1|2@0+ (1,0) [0|3] ""  EOCM_F_FO
 SG_ FVisionObjectIDTrk6 : 7|6@0+ (1,0) [0|63] ""  EOCM_F_FO
 SG_ FVisionConfTrk6 : 36|2@0+ (1,0) [0|3] ""  EOCM_F_FO
 SG_ FVisionAzRateTrk6 : 34|11@0- (0.125,0) [-128|127.875] "deg/s"  EOCM_F_FO
 SG_ FVisionRelLaneTrk6 : 55|2@0+ (1,0) [0|3] ""  EOCM_F_FO
 SG_ FVisionMeasStatTrk6 : 63|2@0+ (1,0) [0|3] ""  EOCM_F_FO
 SG_ FVisionWidthTrk6 : 61|6@0+ (0.25,0) [0|15.75] "m"  EOCM_F_FO

BO_ 1538 LF_SRR_Trace_Data: 8 LFSRR_FO
 SG_ LFSRRYear : 7|8@0+ (1,0) [0|0] ""  EOCM_F_FO
 SG_ LFSRRSerialNmbr : 39|32@0+ (1,0) [0|0] ""  EOCM_F_FO
 SG_ LFSRRJulianDate : 15|24@0+ (1,0) [0|0] ""  EOCM_F_FO

BO_ 1537 R_SRR_Trace_data: 8 RSRR_FO
 SG_ RSRRYear : 7|8@0+ (1,0) [0|0] ""  EOCM_F_FO
 SG_ RSRRSerialNmbr : 39|32@0+ (1,0) [0|0] ""  EOCM_F_FO
 SG_ RSRRJulianDate : 15|24@0+ (1,0) [0|0] ""  EOCM_F_FO

BO_ 1089 F_Vision_Obj_Track_7: 8 VIS2_FO
 SG_ FVisBurstIDTrk7 : 1|2@0+ (1,0) [0|3] ""  EOCM_F_FO
 SG_ FVisionObjectIDTrk7 : 7|6@0+ (1,0) [0|63] ""  EOCM_F_FO
 SG_ FVisionConfTrk7 : 36|2@0+ (1,0) [0|3] ""  EOCM_F_FO
 SG_ FVisionAzRateTrk7 : 34|11@0- (0.125,0) [-128|127.875] "deg/s"  EOCM_F_FO
 SG_ FVisionRelLaneTrk7 : 55|2@0+ (1,0) [0|3] ""  EOCM_F_FO
 SG_ FVisionMeasStatTrk7 : 63|2@0+ (1,0) [0|3] ""  EOCM_F_FO
 SG_ FVisionWidthTrk7 : 61|6@0+ (0.25,0) [0|15.75] "m"  EOCM_F_FO
 SG_ FwdVsnRngTrk7Rev : 16|12@0+ (0.1,0) [0|409.5] "m"  EOCM_F_FO
 SG_ FwdVsnObjTypTr7Rev : 14|4@0+ (1,0) [0|15] ""  EOCM_F_FO
 SG_ FwdVsnAzmthTrk7Rev : 10|10@0- (0.1,0) [-51.2|51.1] "deg"  EOCM_F_FO
 SG_ FwdVsnVertPosTrk7 : 53|6@0+ (0.25,-2) [-2|13.75] "deg"  EOCM_F_FO
 SG_ ObjDirTrk7 : 15|1@0+ (1,0) [0|1] ""  EOCM_F_FO

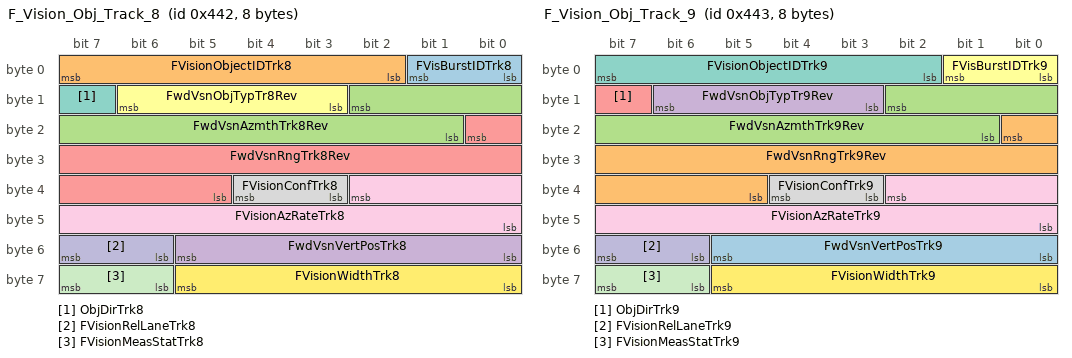
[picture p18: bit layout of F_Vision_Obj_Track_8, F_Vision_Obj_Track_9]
BO_ 1090 F_Vision_Obj_Track_8: 8 VIS2_FO
 SG_ FVisBurstIDTrk8 : 1|2@0+ (1,0) [0|3] ""  EOCM_F_FO
 SG_ FVisionObjectIDTrk8 : 7|6@0+ (1,0) [0|63] ""  EOCM_F_FO
 SG_ FwdVsnAzmthTrk8Rev : 10|10@0- (0.1,0) [-51.2|51.1] "deg"  EOCM_F_FO
 SG_ FwdVsnVertPosTrk8 : 53|6@0+ (0.25,-2) [-2|13.75] "deg"  EOCM_F_FO
 SG_ FwdVsnRngTrk8Rev : 16|12@0+ (0.1,0) [0|409.5] "m"  EOCM_F_FO
 SG_ FwdVsnObjTypTr8Rev : 14|4@0+ (1,0) [0|15] ""  EOCM_F_FO
 SG_ ObjDirTrk8 : 15|1@0+ (1,0) [0|1] ""  EOCM_F_FO
 SG_ FVisionConfTrk8 : 36|2@0+ (1,0) [0|3] ""  EOCM_F_FO
 SG_ FVisionAzRateTrk8 : 34|11@0- (0.125,0) [-128|127.875] "deg/s"  EOCM_F_FO
 SG_ FVisionRelLaneTrk8 : 55|2@0+ (1,0) [0|3] ""  EOCM_F_FO
 SG_ FVisionMeasStatTrk8 : 63|2@0+ (1,0) [0|3] ""  EOCM_F_FO
 SG_ FVisionWidthTrk8 : 61|6@0+ (0.25,0) [0|15.75] "m"  EOCM_F_FO

BO_ 1091 F_Vision_Obj_Track_9: 8 VIS2_FO
 SG_ FwdVsnVertPosTrk9 : 53|6@0+ (0.25,-2) [-2|13.75] "deg"  EOCM_F_FO
 SG_ FwdVsnRngTrk9Rev : 16|12@0+ (0.1,0) [0|409.5] "m"  EOCM_F_FO
 SG_ FwdVsnAzmthTrk9Rev : 10|10@0- (0.1,0) [-51.2|51.1] "deg"  EOCM_F_FO
 SG_ FwdVsnObjTypTr9Rev : 14|4@0+ (1,0) [0|15] ""  EOCM_F_FO
 SG_ ObjDirTrk9 : 15|1@0+ (1,0) [0|1] ""  EOCM_F_FO
 SG_ FVisBurstIDTrk9 : 1|2@0+ (1,0) [0|3] ""  EOCM_F_FO
 SG_ FVisionObjectIDTrk9 : 7|6@0+ (1,0) [0|63] ""  EOCM_F_FO
 SG_ FVisionConfTrk9 : 36|2@0+ (1,0) [0|3] ""  EOCM_F_FO
 SG_ FVisionAzRateTrk9 : 34|11@0- (0.125,0) [-128|127.875] "deg/s"  EOCM_F_FO
 SG_ FVisionRelLaneTrk9 : 55|2@0+ (1,0) [0|3] ""  EOCM_F_FO
 SG_ FVisionMeasStatTrk9 : 63|2@0+ (1,0) [0|3] ""  EOCM_F_FO
 SG_ FVisionWidthTrk9 : 61|6@0+ (0.25,0) [0|15.75] "m"  EOCM_F_FO

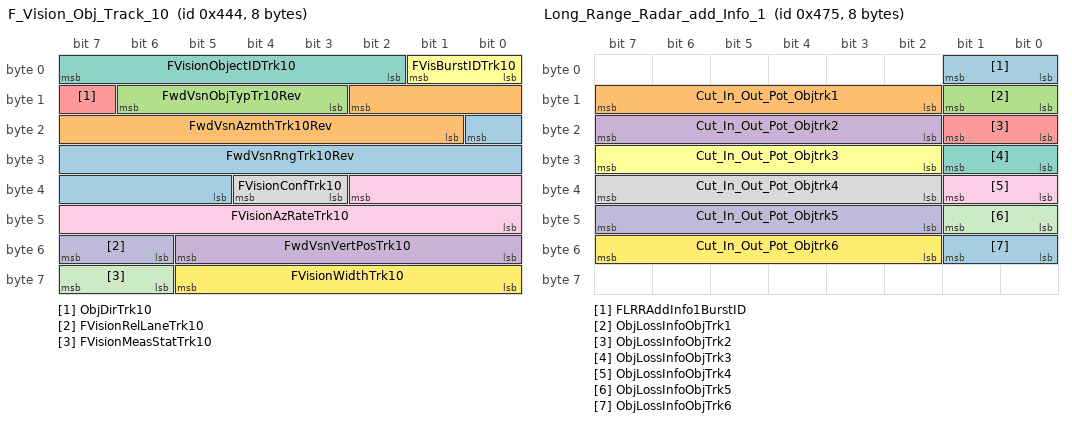
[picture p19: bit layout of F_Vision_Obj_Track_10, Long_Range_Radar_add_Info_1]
BO_ 1092 F_Vision_Obj_Track_10: 8 VIS2_FO
 SG_ FwdVsnRngTrk10Rev : 16|12@0+ (0.1,0) [0|409.5] "m"  EOCM_F_FO
 SG_ FwdVsnAzmthTrk10Rev : 10|10@0- (0.1,0) [-51.2|51.1] "deg"  EOCM_F_FO
 SG_ FwdVsnObjTypTr10Rev : 14|4@0+ (1,0) [0|15] ""  EOCM_F_FO
 SG_ FwdVsnVertPosTrk10 : 53|6@0+ (0.25,-2) [-2|13.75] "deg"  EOCM_F_FO
 SG_ ObjDirTrk10 : 15|1@0+ (1,0) [0|1] ""  EOCM_F_FO
 SG_ FVisBurstIDTrk10 : 1|2@0+ (1,0) [0|3] ""  EOCM_F_FO
 SG_ FVisionObjectIDTrk10 : 7|6@0+ (1,0) [0|63] ""  EOCM_F_FO
 SG_ FVisionConfTrk10 : 36|2@0+ (1,0) [0|3] ""  EOCM_F_FO
 SG_ FVisionAzRateTrk10 : 34|11@0- (0.125,0) [-128|127.875] "deg/s"  EOCM_F_FO
 SG_ FVisionRelLaneTrk10 : 55|2@0+ (1,0) [0|3] ""  EOCM_F_FO
 SG_ FVisionMeasStatTrk10 : 63|2@0+ (1,0) [0|3] ""  EOCM_F_FO
 SG_ FVisionWidthTrk10 : 61|6@0+ (0.25,0) [0|15.75] "m"  EOCM_F_FO

BO_ 1120 F_LRR_Obj_Header: 8 LRR_FO
 SG_ FLRRRollingCount : 7|2@0+ (1,0) [0|3] ""  EOCM_F_FO
 SG_ FLRRModeCmdFdbk : 23|3@0+ (1,0) [0|7] ""  EOCM_F_FO
 SG_ FLRRNumValidTargets : 20|5@0+ (1,0) [0|31] ""  EOCM_F_FO
 SG_ FLRRTimeStampV : 31|1@0+ (1,0) [0|1] ""  EOCM_F_FO
 SG_ FLRRTimeStamp : 2|11@0+ (1,0) [0|2047] "ms"  EOCM_F_FO
 SG_ FLRRRoadTypeInfo : 5|3@0+ (1,0) [0|7] ""  EOCM_F_FO
 SG_ FLRRBurstChecksum : 55|16@0+ (1,0) [0|65535] ""  EOCM_F_FO
 SG_ FLRRDiagSpare : 30|1@0+ (1,0) [0|1] ""  EOCM_F_FO
 SG_ FLRRVltgOutRngLo : 44|1@0+ (1,0) [0|1] ""  EOCM_F_FO
 SG_ FLRRVltgOutRngHi : 43|1@0+ (1,0) [0|1] ""  EOCM_F_FO
 SG_ FLRRSvcAlgnInPrcs : 38|1@0+ (1,0) [0|1] ""  EOCM_F_FO
 SG_ FLRRSnsrBlckd : 45|1@0+ (1,0) [0|1] ""  EOCM_F_FO
 SG_ FLRRSnstvFltPrsntInt : 24|1@0+ (1,0) [0|1] ""  EOCM_F_FO
 SG_ FLRRPlntAlgnInProc : 37|1@0+ (1,0) [0|1] ""  EOCM_F_FO
 SG_ FLRRMsalgnYawRt : 47|1@0+ (1,0) [0|1] ""  EOCM_F_FO
 SG_ FLRRMsalgnYawLt : 46|1@0+ (1,0) [0|1] ""  EOCM_F_FO
 SG_ FLRRLonVelPlsblityFlt : 35|1@0+ (1,0) [0|1] ""  EOCM_F_FO
 SG_ FLRRYawRtPlsblityFlt : 34|1@0+ (1,0) [0|1] ""  EOCM_F_FO
 SG_ FLRRMsalgnPtchUp : 32|1@0+ (1,0) [0|1] ""  EOCM_F_FO
 SG_ FLRRMsalgnPtchDn : 33|1@0+ (1,0) [0|1] ""  EOCM_F_FO
 SG_ FLRRInitDiagCmplt : 40|1@0+ (1,0) [0|1] ""  EOCM_F_FO
 SG_ FLRRHWFltPrsntInt : 25|1@0+ (1,0) [0|1] ""  EOCM_F_FO
 SG_ FLRRExtIntrfrnc : 36|1@0+ (1,0) [0|1] ""  EOCM_F_FO
 SG_ FLRRCANSgnlSpvFld : 29|1@0+ (1,0) [0|1] ""  EOCM_F_FO
 SG_ FLRRCANRxErr : 28|1@0+ (1,0) [0|1] ""  EOCM_F_FO
 SG_ FLRRTunlDtctd : 27|1@0+ (1,0) [0|1] ""  EOCM_F_FO
 SG_ FLRRAmbTmpOutRngLw : 42|1@0+ (1,0) [0|1] ""  EOCM_F_FO
 SG_ FLRRAmbTmpOutRngHi : 41|1@0+ (1,0) [0|1] ""  EOCM_F_FO
 SG_ FLRRAntTngFltPrsnt : 26|1@0+ (1,0) [0|1] ""  EOCM_F_FO
 SG_ FLRRAlgnFltPrsnt : 39|1@0+ (1,0) [0|1] ""  EOCM_F_FO

BO_ 1121 F_LRR_Obj_Track_1: 8 LRR_FO
 SG_ FLRRTrk1BurstID : 63|2@0+ (1,0) [0|3] ""  EOCM_F_FO
 SG_ FLRRTrk1Range : 5|11@0+ (0.125,0) [0|255.875] "m"  EOCM_F_FO
 SG_ FLRRTrk1RangeRate : 10|11@0- (0.125,0) [-128|127.875] "m/s"  EOCM_F_FO
 SG_ FLRRTrk1RangeAccel : 31|9@0- (0.125,0) [-32|31.875] "m/s^2"  EOCM_F_FO
 SG_ FLRRTrk1DynProp : 38|3@0+ (1,0) [0|7] ""  EOCM_F_FO
 SG_ FLRRTrk1Azimuth : 35|12@0- (0.125,0) [-256|255.875] "deg"  EOCM_F_FO
 SG_ FLRRTrk1Width : 55|6@0+ (0.25,0) [0|15.75] "m"  EOCM_F_FO
 SG_ FLRRTrk1MeasStatus : 7|2@0+ (1,0) [0|3] ""  EOCM_F_FO
 SG_ FLRRTrk1ObjectID : 61|6@0+ (1,0) [0|63] ""  EOCM_F_FO
 SG_ FLRRTrk1Conf : 49|2@0+ (1,0) [0|3] ""  EOCM_F_FO

BO_ 1122 F_LRR_Obj_Track_2: 8 LRR_FO
 SG_ FLRRTrk2BurstID : 63|2@0+ (1,0) [0|3] ""  EOCM_F_FO
 SG_ FLRRTrk2Range : 5|11@0+ (0.125,0) [0|255.875] "m"  EOCM_F_FO
 SG_ FLRRTrk2RangeRate : 10|11@0- (0.125,0) [-128|127.875] "m/s"  EOCM_F_FO
 SG_ FLRRTrk2RangeAccel : 31|9@0- (0.125,0) [-32|31.875] "m/s^2"  EOCM_F_FO
 SG_ FLRRTrk2DynProp : 38|3@0+ (1,0) [0|7] ""  EOCM_F_FO
 SG_ FLRRTrk2Azimuth : 35|12@0- (0.125,0) [-256|255.875] "deg"  EOCM_F_FO
 SG_ FLRRTrk2Width : 55|6@0+ (0.25,0) [0|15.75] "m"  EOCM_F_FO
 SG_ FLRRTrk2MeasStatus : 7|2@0+ (1,0) [0|3] ""  EOCM_F_FO
 SG_ FLRRTrk2ObjectID : 61|6@0+ (1,0) [0|63] ""  EOCM_F_FO
 SG_ FLRRTrk2Conf : 49|2@0+ (1,0) [0|3] ""  EOCM_F_FO

BO_ 1123 F_LRR_Obj_Track_3: 8 LRR_FO
 SG_ FLRRTrk3BurstID : 63|2@0+ (1,0) [0|3] ""  EOCM_F_FO
 SG_ FLRRTrk3Range : 5|11@0+ (0.125,0) [0|255.875] "m"  EOCM_F_FO
 SG_ FLRRTrk3RangeRate : 10|11@0- (0.125,0) [-128|127.875] "m/s"  EOCM_F_FO
 SG_ FLRRTrk3RangeAccel : 31|9@0- (0.125,0) [-32|31.875] "m/s^2"  EOCM_F_FO
 SG_ FLRRTrk3DynProp : 38|3@0+ (1,0) [0|7] ""  EOCM_F_FO
 SG_ FLRRTrk3Azimuth : 35|12@0- (0.125,0) [-256|255.875] "deg"  EOCM_F_FO
 SG_ FLRRTrk3Width : 55|6@0+ (0.25,0) [0|15.75] "m"  EOCM_F_FO
 SG_ FLRRTrk3MeasStatus : 7|2@0+ (1,0) [0|3] ""  EOCM_F_FO
 SG_ FLRRTrk3ObjectID : 61|6@0+ (1,0) [0|63] ""  EOCM_F_FO
 SG_ FLRRTrk3Conf : 49|2@0+ (1,0) [0|3] ""  EOCM_F_FO

BO_ 1124 F_LRR_Obj_Track_4: 8 LRR_FO
 SG_ FLRRTrk4BurstID : 63|2@0+ (1,0) [0|3] ""  EOCM_F_FO
 SG_ FLRRTrk4Range : 5|11@0+ (0.125,0) [0|255.875] "m"  EOCM_F_FO
 SG_ FLRRTrk4RangeRate : 10|11@0- (0.125,0) [-128|127.875] "m/s"  EOCM_F_FO
 SG_ FLRRTrk4RangeAccel : 31|9@0- (0.125,0) [-32|31.875] "m/s^2"  EOCM_F_FO
 SG_ FLRRTrk4DynProp : 38|3@0+ (1,0) [0|7] ""  EOCM_F_FO
 SG_ FLRRTrk4Azimuth : 35|12@0- (0.125,0) [-256|255.875] "deg"  EOCM_F_FO
 SG_ FLRRTrk4Width : 55|6@0+ (0.25,0) [0|15.75] "m"  EOCM_F_FO
 SG_ FLRRTrk4MeasStatus : 7|2@0+ (1,0) [0|3] ""  EOCM_F_FO
 SG_ FLRRTrk4ObjectID : 61|6@0+ (1,0) [0|63] ""  EOCM_F_FO
 SG_ FLRRTrk4Conf : 49|2@0+ (1,0) [0|3] ""  EOCM_F_FO

BO_ 1125 F_LRR_Obj_Track_5: 8 LRR_FO
 SG_ FLRRTrk5BurstID : 63|2@0+ (1,0) [0|3] ""  EOCM_F_FO
 SG_ FLRRTrk5Range : 5|11@0+ (0.125,0) [0|255.875] "m"  EOCM_F_FO
 SG_ FLRRTrk5RangeRate : 10|11@0- (0.125,0) [-128|127.875] "m/s"  EOCM_F_FO
 SG_ FLRRTrk5RangeAccel : 31|9@0- (0.125,0) [-32|31.875] "m/s^2"  EOCM_F_FO
 SG_ FLRRTrk5DynProp : 38|3@0+ (1,0) [0|7] ""  EOCM_F_FO
 SG_ FLRRTrk5Azimuth : 35|12@0- (0.125,0) [-256|255.875] "deg"  EOCM_F_FO
 SG_ FLRRTrk5Width : 55|6@0+ (0.25,0) [0|15.75] "m"  EOCM_F_FO
 SG_ FLRRTrk5MeasStatus : 7|2@0+ (1,0) [0|3] ""  EOCM_F_FO
 SG_ FLRRTrk5ObjectID : 61|6@0+ (1,0) [0|63] ""  EOCM_F_FO
 SG_ FLRRTrk5Conf : 49|2@0+ (1,0) [0|3] ""  EOCM_F_FO

BO_ 1126 F_LRR_Obj_Track_6: 8 LRR_FO
 SG_ FLRRTrk6BurstID : 63|2@0+ (1,0) [0|3] ""  EOCM_F_FO
 SG_ FLRRTrk6Range : 5|11@0+ (0.125,0) [0|255.875] "m"  EOCM_F_FO
 SG_ FLRRTrk6RangeRate : 10|11@0- (0.125,0) [-128|127.875] "m/s"  EOCM_F_FO
 SG_ FLRRTrk6Conf : 49|2@0+ (1,0) [0|3] ""  EOCM_F_FO
 SG_ FLRRTrk6RangeAccel : 31|9@0- (0.125,0) [-32|31.875] "m/s^2"  EOCM_F_FO
 SG_ FLRRTrk6DynProp : 38|3@0+ (1,0) [0|7] ""  EOCM_F_FO
 SG_ FLRRTrk6Azimuth : 35|12@0- (0.125,0) [-256|255.875] "deg"  EOCM_F_FO
 SG_ FLRRTrk6Width : 55|6@0+ (0.25,0) [0|15.75] "m"  EOCM_F_FO
 SG_ FLRRTrk6MeasStatus : 7|2@0+ (1,0) [0|3] ""  EOCM_F_FO
 SG_ FLRRTrk6ObjectID : 61|6@0+ (1,0) [0|63] ""  EOCM_F_FO

BO_ 1127 F_LRR_Obj_Track_7: 8 LRR_FO
 SG_ FLRRTrk7Conf : 49|2@0+ (1,0) [0|3] ""  EOCM_F_FO
 SG_ FLRRTrk7BurstID : 63|2@0+ (1,0) [0|3] ""  EOCM_F_FO
 SG_ FLRRTrk7Range : 5|11@0+ (0.125,0) [0|255.875] "m"  EOCM_F_FO
 SG_ FLRRTrk7RangeRate : 10|11@0- (0.125,0) [-128|127.875] "m/s"  EOCM_F_FO
 SG_ FLRRTrk7RangeAccel : 31|9@0- (0.125,0) [-32|31.875] "m/s^2"  EOCM_F_FO
 SG_ FLRRTrk7DynProp : 38|3@0+ (1,0) [0|7] ""  EOCM_F_FO
 SG_ FLRRTrk7Azimuth : 35|12@0- (0.125,0) [-256|255.875] "deg"  EOCM_F_FO
 SG_ FLRRTrk7Width : 55|6@0+ (0.25,0) [0|15.75] "m"  EOCM_F_FO
 SG_ FLRRTrk7MeasStatus : 7|2@0+ (1,0) [0|3] ""  EOCM_F_FO
 SG_ FLRRTrk7ObjectID : 61|6@0+ (1,0) [0|63] ""  EOCM_F_FO

BO_ 1128 F_LRR_Obj_Track_8: 8 LRR_FO
 SG_ FLRRTrk8Conf : 49|2@0+ (1,0) [0|3] ""  EOCM_F_FO
 SG_ FLRRTrk8BurstID : 63|2@0+ (1,0) [0|3] ""  EOCM_F_FO
 SG_ FLRRTrk8Range : 5|11@0+ (0.125,0) [0|255.875] "m"  EOCM_F_FO
 SG_ FLRRTrk8RangeRate : 10|11@0- (0.125,0) [-128|127.875] "m/s"  EOCM_F_FO
 SG_ FLRRTrk8RangeAccel : 31|9@0- (0.125,0) [-32|31.875] "m/s^2"  EOCM_F_FO
 SG_ FLRRTrk8DynProp : 38|3@0+ (1,0) [0|7] ""  EOCM_F_FO
 SG_ FLRRTrk8Azimuth : 35|12@0- (0.125,0) [-256|255.875] "deg"  EOCM_F_FO
 SG_ FLRRTrk8Width : 55|6@0+ (0.25,0) [0|15.75] "m"  EOCM_F_FO
 SG_ FLRRTrk8MeasStatus : 7|2@0+ (1,0) [0|3] ""  EOCM_F_FO
 SG_ FLRRTrk8ObjectID : 61|6@0+ (1,0) [0|63] ""  EOCM_F_FO

BO_ 1129 F_LRR_Obj_Track_9: 8 LRR_FO
 SG_ FLRRTrk9Conf : 49|2@0+ (1,0) [0|3] ""  EOCM_F_FO
 SG_ FLRRTrk9BurstID : 63|2@0+ (1,0) [0|3] ""  EOCM_F_FO
 SG_ FLRRTrk9Range : 5|11@0+ (0.125,0) [0|255.875] "m"  EOCM_F_FO
 SG_ FLRRTrk9RangeRate : 10|11@0- (0.125,0) [-128|127.875] "m/s"  EOCM_F_FO
 SG_ FLRRTrk9RangeAccel : 31|9@0- (0.125,0) [-32|31.875] "m/s^2"  EOCM_F_FO
 SG_ FLRRTrk9DynProp : 38|3@0+ (1,0) [0|7] ""  EOCM_F_FO
 SG_ FLRRTrk9Azimuth : 35|12@0- (0.125,0) [-256|255.875] "deg"  EOCM_F_FO
 SG_ FLRRTrk9Width : 55|6@0+ (0.25,0) [0|15.75] "m"  EOCM_F_FO
 SG_ FLRRTrk9MeasStatus : 7|2@0+ (1,0) [0|3] ""  EOCM_F_FO
 SG_ FLRRTrk9ObjectID : 61|6@0+ (1,0) [0|63] ""  EOCM_F_FO

BO_ 1130 F_LRR_Obj_Track_10: 8 LRR_FO
 SG_ FLRRTrk10Conf : 49|2@0+ (1,0) [0|3] ""  EOCM_F_FO
 SG_ FLRRTrk10BurstID : 63|2@0+ (1,0) [0|3] ""  EOCM_F_FO
 SG_ FLRRTrk10Range : 5|11@0+ (0.125,0) [0|255.875] "m"  EOCM_F_FO
 SG_ FLRRTrk10RangeRate : 10|11@0- (0.125,0) [-128|127.875] "m/s"  EOCM_F_FO
 SG_ FLRRTrk10RangeAccel : 31|9@0- (0.125,0) [-32|31.875] "m/s^2"  EOCM_F_FO
 SG_ FLRRTrk10DynProp : 38|3@0+ (1,0) [0|7] ""  EOCM_F_FO
 SG_ FLRRTrk10Azimuth : 35|12@0- (0.125,0) [-256|255.875] "deg"  EOCM_F_FO
 SG_ FLRRTrk10Width : 55|6@0+ (0.25,0) [0|15.75] "m"  EOCM_F_FO
 SG_ FLRRTrk10MeasStatus : 7|2@0+ (1,0) [0|3] ""  EOCM_F_FO
 SG_ FLRRTrk10ObjectID : 61|6@0+ (1,0) [0|63] ""  EOCM_F_FO

BO_ 1131 F_LRR_Obj_Track_11: 8 LRR_FO
 SG_ FLRRTrk11Conf : 49|2@0+ (1,0) [0|3] ""  EOCM_F_FO
 SG_ FLRRTrk11BurstID : 63|2@0+ (1,0) [0|3] ""  EOCM_F_FO
 SG_ FLRRTrk11Range : 5|11@0+ (0.125,0) [0|255.875] "m"  EOCM_F_FO
 SG_ FLRRTrk11RangeRate : 10|11@0- (0.125,0) [-128|127.875] "m/s"  EOCM_F_FO
 SG_ FLRRTrk11RangeAccel : 31|9@0- (0.125,0) [-32|31.875] "m/s^2"  EOCM_F_FO
 SG_ FLRRTrk11DynProp : 38|3@0+ (1,0) [0|7] ""  EOCM_F_FO
 SG_ FLRRTrk11Azimuth : 35|12@0- (0.125,0) [-256|255.875] "deg"  EOCM_F_FO
 SG_ FLRRTrk11Width : 55|6@0+ (0.25,0) [0|15.75] "m"  EOCM_F_FO
 SG_ FLRRTrk11MeasStatus : 7|2@0+ (1,0) [0|3] ""  EOCM_F_FO
 SG_ FLRRTrk11ObjectID : 61|6@0+ (1,0) [0|63] ""  EOCM_F_FO

BO_ 1132 F_LRR_Obj_Track_12: 8 LRR_FO
 SG_ FLRRTrk12Conf : 49|2@0+ (1,0) [0|3] ""  EOCM_F_FO
 SG_ FLRRTrk12BurstID : 63|2@0+ (1,0) [0|3] ""  EOCM_F_FO
 SG_ FLRRTrk12Range : 5|11@0+ (0.125,0) [0|255.875] "m"  EOCM_F_FO
 SG_ FLRRTrk12RangeRate : 10|11@0- (0.125,0) [-128|127.875] "m/s"  EOCM_F_FO
 SG_ FLRRTrk12RangeAccel : 31|9@0- (0.125,0) [-32|31.875] "m/s^2"  EOCM_F_FO
 SG_ FLRRTrk12DynProp : 38|3@0+ (1,0) [0|7] ""  EOCM_F_FO
 SG_ FLRRTrk12Azimuth : 35|12@0- (0.125,0) [-256|255.875] "deg"  EOCM_F_FO
 SG_ FLRRTrk12Width : 55|6@0+ (0.25,0) [0|15.75] "m"  EOCM_F_FO
 SG_ FLRRTrk12MeasStatus : 7|2@0+ (1,0) [0|3] ""  EOCM_F_FO
 SG_ FLRRTrk12ObjectID : 61|6@0+ (1,0) [0|63] ""  EOCM_F_FO

BO_ 1133 F_LRR_Obj_Track_13: 8 LRR_FO
 SG_ FLRRTrk13Conf : 49|2@0+ (1,0) [0|3] ""  EOCM_F_FO
 SG_ FLRRTrk13BurstID : 63|2@0+ (1,0) [0|3] ""  EOCM_F_FO
 SG_ FLRRTrk13Range : 5|11@0+ (0.125,0) [0|255.875] "m"  EOCM_F_FO
 SG_ FLRRTrk13RangeRate : 10|11@0- (0.125,0) [-128|127.875] "m/s"  EOCM_F_FO
 SG_ FLRRTrk13RangeAccel : 31|9@0- (0.125,0) [-32|31.875] "m/s^2"  EOCM_F_FO
 SG_ FLRRTrk13DynProp : 38|3@0+ (1,0) [0|7] ""  EOCM_F_FO
 SG_ FLRRTrk13Azimuth : 35|12@0- (0.125,0) [-256|255.875] "deg"  EOCM_F_FO
 SG_ FLRRTrk13Width : 55|6@0+ (0.25,0) [0|15.75] "m"  EOCM_F_FO
 SG_ FLRRTrk13MeasStatus : 7|2@0+ (1,0) [0|3] ""  EOCM_F_FO
 SG_ FLRRTrk13ObjectID : 61|6@0+ (1,0) [0|63] ""  EOCM_F_FO

BO_ 1134 F_LRR_Obj_Track_14: 8 LRR_FO
 SG_ FLRRTrk14Conf : 49|2@0+ (1,0) [0|3] ""  EOCM_F_FO
 SG_ FLRRTrk14BurstID : 63|2@0+ (1,0) [0|3] ""  EOCM_F_FO
 SG_ FLRRTrk14Range : 5|11@0+ (0.125,0) [0|255.875] "m"  EOCM_F_FO
 SG_ FLRRTrk14RangeRate : 10|11@0- (0.125,0) [-128|127.875] "m/s"  EOCM_F_FO
 SG_ FLRRTrk14RangeAccel : 31|9@0- (0.125,0) [-32|31.875] "m/s^2"  EOCM_F_FO
 SG_ FLRRTrk14DynProp : 38|3@0+ (1,0) [0|7] ""  EOCM_F_FO
 SG_ FLRRTrk14Azimuth : 35|12@0- (0.125,0) [-256|255.875] "deg"  EOCM_F_FO
 SG_ FLRRTrk14Width : 55|6@0+ (0.25,0) [0|15.75] "m"  EOCM_F_FO
 SG_ FLRRTrk14MeasStatus : 7|2@0+ (1,0) [0|3] ""  EOCM_F_FO
 SG_ FLRRTrk14ObjectID : 61|6@0+ (1,0) [0|63] ""  EOCM_F_FO

BO_ 1135 F_LRR_Obj_Track_15: 8 LRR_FO
 SG_ FLRRTrk15Width : 55|6@0+ (0.25,0) [0|15.75] "m"  EOCM_F_FO
 SG_ FLRRTrk15MeasStatus : 7|2@0+ (1,0) [0|3] ""  EOCM_F_FO
 SG_ FLRRTrk15Conf : 49|2@0+ (1,0) [0|3] ""  EOCM_F_FO
 SG_ FLRRTrk15ObjectID : 61|6@0+ (1,0) [0|63] ""  EOCM_F_FO
 SG_ FLRRTrk15BurstID : 63|2@0+ (1,0) [0|3] ""  EOCM_F_FO
 SG_ FLRRTrk15Range : 5|11@0+ (0.125,0) [0|255.875] "m"  EOCM_F_FO
 SG_ FLRRTrk15RangeRate : 10|11@0- (0.125,0) [-128|127.875] "m/s"  EOCM_F_FO
 SG_ FLRRTrk15RangeAccel : 31|9@0- (0.125,0) [-32|31.875] "m/s^2"  EOCM_F_FO
 SG_ FLRRTrk15DynProp : 38|3@0+ (1,0) [0|7] ""  EOCM_F_FO
 SG_ FLRRTrk15Azimuth : 35|12@0- (0.125,0) [-256|255.875] "deg"  EOCM_F_FO

BO_ 1136 F_LRR_Obj_Track_16: 8 LRR_FO
 SG_ FLRRTrk16Conf : 49|2@0+ (1,0) [0|3] ""  EOCM_F_FO
 SG_ FLRRTrk16BurstID : 63|2@0+ (1,0) [0|3] ""  EOCM_F_FO
 SG_ FLRRTrk16Range : 5|11@0+ (0.125,0) [0|255.875] "m"  EOCM_F_FO
 SG_ FLRRTrk16RangeRate : 10|11@0- (0.125,0) [-128|127.875] "m/s"  EOCM_F_FO
 SG_ FLRRTrk16RangeAccel : 31|9@0- (0.125,0) [-32|31.875] "m/s^2"  EOCM_F_FO
 SG_ FLRRTrk16DynProp : 38|3@0+ (1,0) [0|7] ""  EOCM_F_FO
 SG_ FLRRTrk16Azimuth : 35|12@0- (0.125,0) [-256|255.875] "deg"  EOCM_F_FO
 SG_ FLRRTrk16Width : 55|6@0+ (0.25,0) [0|15.75] "m"  EOCM_F_FO
 SG_ FLRRTrk16MeasStatus : 7|2@0+ (1,0) [0|3] ""  EOCM_F_FO
 SG_ FLRRTrk16ObjectID : 61|6@0+ (1,0) [0|63] ""  EOCM_F_FO

BO_ 1137 F_LRR_Obj_Track_17: 8 LRR_FO
 SG_ FLRRTrk17Conf : 49|2@0+ (1,0) [0|3] ""  EOCM_F_FO
 SG_ FLRRTrk17BurstID : 63|2@0+ (1,0) [0|3] ""  EOCM_F_FO
 SG_ FLRRTrk17Range : 5|11@0+ (0.125,0) [0|255.875] "m"  EOCM_F_FO
 SG_ FLRRTrk17RangeRate : 10|11@0- (0.125,0) [-128|127.875] "m/s"  EOCM_F_FO
 SG_ FLRRTrk17RangeAccel : 31|9@0- (0.125,0) [-32|31.875] "m/s^2"  EOCM_F_FO
 SG_ FLRRTrk17DynProp : 38|3@0+ (1,0) [0|7] ""  EOCM_F_FO
 SG_ FLRRTrk17Azimuth : 35|12@0- (0.125,0) [-256|255.875] "deg"  EOCM_F_FO
 SG_ FLRRTrk17Width : 55|6@0+ (0.25,0) [0|15.75] "m"  EOCM_F_FO
 SG_ FLRRTrk17MeasStatus : 7|2@0+ (1,0) [0|3] ""  EOCM_F_FO
 SG_ FLRRTrk17ObjectID : 61|6@0+ (1,0) [0|63] ""  EOCM_F_FO

BO_ 1138 F_LRR_Obj_Track_18: 8 LRR_FO
 SG_ FLRRTrk18Conf : 49|2@0+ (1,0) [0|3] ""  EOCM_F_FO
 SG_ FLRRTrk18BurstID : 63|2@0+ (1,0) [0|3] ""  EOCM_F_FO
 SG_ FLRRTrk18Range : 5|11@0+ (0.125,0) [0|255.875] "m"  EOCM_F_FO
 SG_ FLRRTrk18RangeRate : 10|11@0- (0.125,0) [-128|127.875] "m/s"  EOCM_F_FO
 SG_ FLRRTrk18RangeAccel : 31|9@0- (0.125,0) [-32|31.875] "m/s^2"  EOCM_F_FO
 SG_ FLRRTrk18DynProp : 38|3@0+ (1,0) [0|7] ""  EOCM_F_FO
 SG_ FLRRTrk18Azimuth : 35|12@0- (0.125,0) [-256|255.875] "deg"  EOCM_F_FO
 SG_ FLRRTrk18Width : 55|6@0+ (0.25,0) [0|15.75] "m"  EOCM_F_FO
 SG_ FLRRTrk18MeasStatus : 7|2@0+ (1,0) [0|3] ""  EOCM_F_FO
 SG_ FLRRTrk18ObjectID : 61|6@0+ (1,0) [0|63] ""  EOCM_F_FO

BO_ 1139 F_LRR_Obj_Track_19: 8 LRR_FO
 SG_ FLRRTrk19Conf : 49|2@0+ (1,0) [0|3] ""  EOCM_F_FO
 SG_ FLRRTrk19BurstID : 63|2@0+ (1,0) [0|3] ""  EOCM_F_FO
 SG_ FLRRTrk19Range : 5|11@0+ (0.125,0) [0|255.875] "m"  EOCM_F_FO
 SG_ FLRRTrk19RangeRate : 10|11@0- (0.125,0) [-128|127.875] "m/s"  EOCM_F_FO
 SG_ FLRRTrk19RangeAccel : 31|9@0- (0.125,0) [-32|31.875] "m/s^2"  EOCM_F_FO
 SG_ FLRRTrk19DynProp : 38|3@0+ (1,0) [0|7] ""  EOCM_F_FO
 SG_ FLRRTrk19Azimuth : 35|12@0- (0.125,0) [-256|255.875] "deg"  EOCM_F_FO
 SG_ FLRRTrk19Width : 55|6@0+ (0.25,0) [0|15.75] "m"  EOCM_F_FO
 SG_ FLRRTrk19MeasStatus : 7|2@0+ (1,0) [0|3] ""  EOCM_F_FO
 SG_ FLRRTrk19ObjectID : 61|6@0+ (1,0) [0|63] ""  EOCM_F_FO

BO_ 1140 F_LRR_Obj_Track_20: 8 LRR_FO
 SG_ FLRRTrk20Conf : 49|2@0+ (1,0) [0|3] ""  EOCM_F_FO
 SG_ FLRRTrk20BurstID : 63|2@0+ (1,0) [0|3] ""  EOCM_F_FO
 SG_ FLRRTrk20Range : 5|11@0+ (0.125,0) [0|255.875] "m"  EOCM_F_FO
 SG_ FLRRTrk20RangeRate : 10|11@0- (0.125,0) [-128|127.875] "m/s"  EOCM_F_FO
 SG_ FLRRTrk20RangeAccel : 31|9@0- (0.125,0) [-32|31.875] "m/s^2"  EOCM_F_FO
 SG_ FLRRTrk20DynProp : 38|3@0+ (1,0) [0|7] ""  EOCM_F_FO
 SG_ FLRRTrk20Azimuth : 35|12@0- (0.125,0) [-256|255.875] "deg"  EOCM_F_FO
 SG_ FLRRTrk20Width : 55|6@0+ (0.25,0) [0|15.75] "m"  EOCM_F_FO
 SG_ FLRRTrk20MeasStatus : 7|2@0+ (1,0) [0|3] ""  EOCM_F_FO
 SG_ FLRRTrk20ObjectID : 61|6@0+ (1,0) [0|63] ""  EOCM_F_FO

BO_ 1141 Long_Range_Radar_add_Info_1: 8 LRR_FO
 SG_ FLRRAddInfo1BurstID : 1|2@0+ (1,0) [0|3] ""  EOCM_F_FO
 SG_ Cut_In_Out_Pot_Objtrk1 : 15|6@0+ (0.02,0) [0|1.26] ""  EOCM_F_FO
 SG_ ObjLossInfoObjTrk1 : 9|2@0+ (1,0) [0|3] ""  EOCM_F_FO
 SG_ Cut_In_Out_Pot_Objtrk2 : 23|6@0+ (0.02,0) [0|1.26] ""  EOCM_F_FO
 SG_ ObjLossInfoObjTrk2 : 17|2@0+ (1,0) [0|3] ""  EOCM_F_FO
 SG_ Cut_In_Out_Pot_Objtrk3 : 31|6@0+ (0.02,0) [0|1.26] ""  EOCM_F_FO
 SG_ ObjLossInfoObjTrk3 : 25|2@0+ (1,0) [0|3] ""  EOCM_F_FO
 SG_ Cut_In_Out_Pot_Objtrk4 : 39|6@0+ (0.02,0) [0|1.26] ""  EOCM_F_FO
 SG_ ObjLossInfoObjTrk4 : 33|2@0+ (1,0) [0|3] ""  EOCM_F_FO
 SG_ Cut_In_Out_Pot_Objtrk5 : 47|6@0+ (0.02,0) [0|1.26] ""  EOCM_F_FO
 SG_ ObjLossInfoObjTrk5 : 41|2@0+ (1,0) [0|3] ""  EOCM_F_FO
 SG_ Cut_In_Out_Pot_Objtrk6 : 55|6@0+ (0.02,0) [0|1.26] ""  EOCM_F_FO
 SG_ ObjLossInfoObjTrk6 : 49|2@0+ (1,0) [0|3] ""  EOCM_F_FO

BO_ 1321 F_Fwd_Fus_Obj_TrackB_9: 7 EOCM_F_FO
 SG_ FwdFusTrkBAnlgRlLn9 : 46|8@0- (0.1,0) [-12.8|12.7] ""  Dummy_FO
 SG_ FwdFusTrkB9RollingCnt : 7|2@0+ (1,0) [0|3] ""  Dummy_FO
 SG_ FwdFusTrkB9Width : 5|6@0+ (0.25,0) [0|15.75] "m"  Dummy_FO
 SG_ FwdFusTrkB9MsgIndex : 15|4@0+ (1,0) [0|15] ""  Dummy_FO
 SG_ FwdFusTrkB9DynProp : 11|3@0+ (1,0) [0|7] ""  Dummy_FO
 SG_ FwdFusTrkB9RelLnAccl : 8|9@0- (0.125,0) [-32|31.875] "m/s^2"  Dummy_FO
 SG_ FwdFusTrkB9RelLane : 31|2@0+ (1,0) [0|3] ""  Dummy_FO
 SG_ FwdFusTrkB9Height : 54|6@0+ (0.25,0) [0|15.75] "m"  Dummy_FO
 SG_ FFusTrkB9ObjSrcLFSrr : 29|1@0+ (1,0) [0|1] ""  Dummy_FO
 SG_ FFusTrkB9ObjSrcLCSrr : 28|1@0+ (1,0) [0|1] ""  Dummy_FO
 SG_ FFusTrkB9ObjSrcRCSrr : 27|1@0+ (1,0) [0|1] ""  Dummy_FO
 SG_ FFusTrkB9ObjSrcRFSrr : 26|1@0+ (1,0) [0|1] ""  Dummy_FO
 SG_ FFusTrkB9ObjSrcVIs : 25|1@0+ (1,0) [0|1] ""  Dummy_FO
 SG_ FwdFusTrkB9ObjSrcLrr : 24|1@0+ (1,0) [0|1] ""  Dummy_FO
 SG_ FwdFusTrkB9NmCycTrkd : 39|3@0+ (1,0) [0|7] ""  Dummy_FO
 SG_ FwdFusTrkB9LatPosDev : 36|3@0+ (1,0) [0|7] ""  Dummy_FO
 SG_ FwdFusTrkB9LngPosDev : 33|3@0+ (1,0) [0|7] ""  Dummy_FO

BO_ 1320 F_Fwd_Fus_Obj_TrackB_8: 7 EOCM_F_FO
 SG_ FwdFusTrkBAnlgRlLn8 : 46|8@0- (0.1,0) [-12.8|12.7] ""  Dummy_FO
 SG_ FwdFusTrkB8RollingCnt : 7|2@0+ (1,0) [0|3] ""  Dummy_FO
 SG_ FwdFusTrkB8Width : 5|6@0+ (0.25,0) [0|15.75] "m"  Dummy_FO
 SG_ FwdFusTrkB8MsgIndex : 15|4@0+ (1,0) [0|15] ""  Dummy_FO
 SG_ FwdFusTrkB8DynProp : 11|3@0+ (1,0) [0|7] ""  Dummy_FO
 SG_ FwdFusTrkB8RelLnAccl : 8|9@0- (0.125,0) [-32|31.875] "m/s^2"  Dummy_FO
 SG_ FwdFusTrkB8RelLane : 31|2@0+ (1,0) [0|3] ""  Dummy_FO
 SG_ FwdFusTrkB8Height : 54|6@0+ (0.25,0) [0|15.75] "m"  Dummy_FO
 SG_ FFusTrkB8ObjSrcLFSrr : 29|1@0+ (1,0) [0|1] ""  Dummy_FO
 SG_ FFusTrkB8ObjSrcLCSrr : 28|1@0+ (1,0) [0|1] ""  Dummy_FO
 SG_ FFusTrkB8ObjSrcRCSrr : 27|1@0+ (1,0) [0|1] ""  Dummy_FO
 SG_ FFusTrkB8ObjSrcRFSrr : 26|1@0+ (1,0) [0|1] ""  Dummy_FO
 SG_ FFusTrkB8ObjSrcVIs : 25|1@0+ (1,0) [0|1] ""  Dummy_FO
 SG_ FwdFusTrkB8ObjSrcLrr : 24|1@0+ (1,0) [0|1] ""  Dummy_FO
 SG_ FwdFusTrkB8NmCycTrkd : 39|3@0+ (1,0) [0|7] ""  Dummy_FO
 SG_ FwdFusTrkB8LatPosDev : 36|3@0+ (1,0) [0|7] ""  Dummy_FO
 SG_ FwdFusTrkB8LngPosDev : 33|3@0+ (1,0) [0|7] ""  Dummy_FO

BO_ 1319 F_Fwd_Fus_Obj_TrackB_7: 7 EOCM_F_FO
 SG_ FwdFusTrkBAnlgRlLn7 : 46|8@0- (0.1,0) [-12.8|12.7] ""  Dummy_FO
 SG_ FwdFusTrkB7RollingCnt : 7|2@0+ (1,0) [0|3] ""  Dummy_FO
 SG_ FwdFusTrkB7Width : 5|6@0+ (0.25,0) [0|15.75] "m"  Dummy_FO
 SG_ FwdFusTrkB7MsgIndex : 15|4@0+ (1,0) [0|15] ""  Dummy_FO
 SG_ FwdFusTrkB7DynProp : 11|3@0+ (1,0) [0|7] ""  Dummy_FO
 SG_ FwdFusTrkB7RelLnAccl : 8|9@0- (0.125,0) [-32|31.875] "m/s^2"  Dummy_FO
 SG_ FwdFusTrkB7RelLane : 31|2@0+ (1,0) [0|3] ""  Dummy_FO
 SG_ FwdFusTrkB7Height : 54|6@0+ (0.25,0) [0|15.75] "m"  Dummy_FO
 SG_ FFusTrkB7ObjSrcLFSrr : 29|1@0+ (1,0) [0|1] ""  Dummy_FO
 SG_ FFusTrkB7ObjSrcLCSrr : 28|1@0+ (1,0) [0|1] ""  Dummy_FO
 SG_ FFusTrkB7ObjSrcRCSrr : 27|1@0+ (1,0) [0|1] ""  Dummy_FO
 SG_ FFusTrkB7ObjSrcRFSrr : 26|1@0+ (1,0) [0|1] ""  Dummy_FO
 SG_ FFusTrkB7ObjSrcVIs : 25|1@0+ (1,0) [0|1] ""  Dummy_FO
 SG_ FwdFusTrkB7ObjSrcLrr : 24|1@0+ (1,0) [0|1] ""  Dummy_FO
 SG_ FwdFusTrkB7NmCycTrkd : 39|3@0+ (1,0) [0|7] ""  Dummy_FO
 SG_ FwdFusTrkB7LatPosDev : 36|3@0+ (1,0) [0|7] ""  Dummy_FO
 SG_ FwdFusTrkB7LngPosDev : 33|3@0+ (1,0) [0|7] ""  Dummy_FO

BO_ 1318 F_Fwd_Fus_Obj_TrackB_6: 7 EOCM_F_FO
 SG_ FwdFusTrkBAnlgRlLn6 : 46|8@0- (0.1,0) [-12.8|12.7] ""  Dummy_FO
 SG_ FwdFusTrkB6RollingCnt : 7|2@0+ (1,0) [0|3] ""  Dummy_FO
 SG_ FwdFusTrkB6Width : 5|6@0+ (0.25,0) [0|15.75] "m"  Dummy_FO
 SG_ FwdFusTrkB6MsgIndex : 15|4@0+ (1,0) [0|15] ""  Dummy_FO
 SG_ FwdFusTrkB6DynProp : 11|3@0+ (1,0) [0|7] ""  Dummy_FO
 SG_ FwdFusTrkB6RelLnAccl : 8|9@0- (0.125,0) [-32|31.875] "m/s^2"  Dummy_FO
 SG_ FwdFusTrkB6RelLane : 31|2@0+ (1,0) [0|3] ""  Dummy_FO
 SG_ FwdFusTrkB6Height : 54|6@0+ (0.25,0) [0|15.75] "m"  Dummy_FO
 SG_ FFusTrkB6ObjSrcLFSrr : 29|1@0+ (1,0) [0|1] ""  Dummy_FO
 SG_ FFusTrkB6ObjSrcLCSrr : 28|1@0+ (1,0) [0|1] ""  Dummy_FO
 SG_ FFusTrkB6ObjSrcRCSrr : 27|1@0+ (1,0) [0|1] ""  Dummy_FO
 SG_ FFusTrkB6ObjSrcRFSrr : 26|1@0+ (1,0) [0|1] ""  Dummy_FO
 SG_ FFusTrkB6ObjSrcVIs : 25|1@0+ (1,0) [0|1] ""  Dummy_FO
 SG_ FwdFusTrkB6ObjSrcLrr : 24|1@0+ (1,0) [0|1] ""  Dummy_FO
 SG_ FwdFusTrkB6NmCycTrkd : 39|3@0+ (1,0) [0|7] ""  Dummy_FO
 SG_ FwdFusTrkB6LatPosDev : 36|3@0+ (1,0) [0|7] ""  Dummy_FO
 SG_ FwdFusTrkB6LngPosDev : 33|3@0+ (1,0) [0|7] ""  Dummy_FO

BO_ 1317 F_Fwd_Fus_Obj_TrackB_5: 7 EOCM_F_FO
 SG_ FwdFusTrkBAnlgRlLn5 : 46|8@0- (0.1,0) [-12.8|12.7] ""  Dummy_FO
 SG_ FwdFusTrkB5RollingCnt : 7|2@0+ (1,0) [0|3] ""  Dummy_FO
 SG_ FwdFusTrkB5Width : 5|6@0+ (0.25,0) [0|15.75] "m"  Dummy_FO
 SG_ FwdFusTrkB5MsgIndex : 15|4@0+ (1,0) [0|15] ""  Dummy_FO
 SG_ FwdFusTrkB5DynProp : 11|3@0+ (1,0) [0|7] ""  Dummy_FO
 SG_ FwdFusTrkB5RelLnAccl : 8|9@0- (0.125,0) [-32|31.875] "m/s^2"  Dummy_FO
 SG_ FwdFusTrkB5RelLane : 31|2@0+ (1,0) [0|3] ""  Dummy_FO
 SG_ FwdFusTrkB5Height : 54|6@0+ (0.25,0) [0|15.75] "m"  Dummy_FO
 SG_ FFusTrkB5ObjSrcLFSrr : 29|1@0+ (1,0) [0|1] ""  Dummy_FO
 SG_ FFusTrkB5ObjSrcLCSrr : 28|1@0+ (1,0) [0|1] ""  Dummy_FO
 SG_ FFusTrkB5ObjSrcRCSrr : 27|1@0+ (1,0) [0|1] ""  Dummy_FO
 SG_ FFusTrkB5ObjSrcRFSrr : 26|1@0+ (1,0) [0|1] ""  Dummy_FO
 SG_ FFusTrkB5ObjSrcVIs : 25|1@0+ (1,0) [0|1] ""  Dummy_FO
 SG_ FwdFusTrkB5ObjSrcLrr : 24|1@0+ (1,0) [0|1] ""  Dummy_FO
 SG_ FwdFusTrkB5NmCycTrkd : 39|3@0+ (1,0) [0|7] ""  Dummy_FO
 SG_ FwdFusTrkB5LatPosDev : 36|3@0+ (1,0) [0|7] ""  Dummy_FO
 SG_ FwdFusTrkB5LngPosDev : 33|3@0+ (1,0) [0|7] ""  Dummy_FO

BO_ 1316 F_Fwd_Fus_Obj_TrackB_4: 7 EOCM_F_FO
 SG_ FwdFusTrkBAnlgRlLn4 : 46|8@0- (0.1,0) [-12.8|12.7] ""  Dummy_FO
 SG_ FwdFusTrkB4RollingCnt : 7|2@0+ (1,0) [0|3] ""  Dummy_FO
 SG_ FwdFusTrkB4Width : 5|6@0+ (0.25,0) [0|15.75] "m"  Dummy_FO
 SG_ FwdFusTrkB4MsgIndex : 15|4@0+ (1,0) [0|15] ""  Dummy_FO
 SG_ FwdFusTrkB4DynProp : 11|3@0+ (1,0) [0|7] ""  Dummy_FO
 SG_ FwdFusTrkB4RelLnAccl : 8|9@0- (0.125,0) [-32|31.875] "m/s^2"  Dummy_FO
 SG_ FwdFusTrkB4RelLane : 31|2@0+ (1,0) [0|3] ""  Dummy_FO
 SG_ FwdFusTrkB4Height : 54|6@0+ (0.25,0) [0|15.75] "m"  Dummy_FO
 SG_ FFusTrkB4ObjSrcLFSrr : 29|1@0+ (1,0) [0|1] ""  Dummy_FO
 SG_ FFusTrkB4ObjSrcLCSrr : 28|1@0+ (1,0) [0|1] ""  Dummy_FO
 SG_ FFusTrkB4ObjSrcRCSrr : 27|1@0+ (1,0) [0|1] ""  Dummy_FO
 SG_ FFusTrkB4ObjSrcRFSrr : 26|1@0+ (1,0) [0|1] ""  Dummy_FO
 SG_ FFusTrkB4ObjSrcVIs : 25|1@0+ (1,0) [0|1] ""  Dummy_FO
 SG_ FwdFusTrkB4ObjSrcLrr : 24|1@0+ (1,0) [0|1] ""  Dummy_FO
 SG_ FwdFusTrkB4NmCycTrkd : 39|3@0+ (1,0) [0|7] ""  Dummy_FO
 SG_ FwdFusTrkB4LatPosDev : 36|3@0+ (1,0) [0|7] ""  Dummy_FO
 SG_ FwdFusTrkB4LngPosDev : 33|3@0+ (1,0) [0|7] ""  Dummy_FO

BO_ 1315 F_Fwd_Fus_Obj_TrackB_3: 7 EOCM_F_FO
 SG_ FwdFusTrkBAnlgRlLn3 : 46|8@0- (0.1,0) [-12.8|12.7] ""  Dummy_FO
 SG_ FwdFusTrkB3RollingCnt : 7|2@0+ (1,0) [0|3] ""  Dummy_FO
 SG_ FwdFusTrkB3Width : 5|6@0+ (0.25,0) [0|15.75] "m"  Dummy_FO
 SG_ FwdFusTrkB3MsgIndex : 15|4@0+ (1,0) [0|15] ""  Dummy_FO
 SG_ FwdFusTrkB3DynProp : 11|3@0+ (1,0) [0|7] ""  Dummy_FO
 SG_ FwdFusTrkB3RelLnAccl : 8|9@0- (0.125,0) [-32|31.875] "m/s^2"  Dummy_FO
 SG_ FwdFusTrkB3RelLane : 31|2@0+ (1,0) [0|3] ""  Dummy_FO
 SG_ FwdFusTrkB3Height : 54|6@0+ (0.25,0) [0|15.75] "m"  Dummy_FO
 SG_ FFusTrkB3ObjSrcLFSrr : 29|1@0+ (1,0) [0|1] ""  Dummy_FO
 SG_ FFusTrkB3ObjSrcLCSrr : 28|1@0+ (1,0) [0|1] ""  Dummy_FO
 SG_ FFusTrkB3ObjSrcRCSrr : 27|1@0+ (1,0) [0|1] ""  Dummy_FO
 SG_ FFusTrkB3ObjSrcRFSrr : 26|1@0+ (1,0) [0|1] ""  Dummy_FO
 SG_ FFusTrkB3ObjSrcVIs : 25|1@0+ (1,0) [0|1] ""  Dummy_FO
 SG_ FwdFusTrkB3ObjSrcLrr : 24|1@0+ (1,0) [0|1] ""  Dummy_FO
 SG_ FwdFusTrkB3NmCycTrkd : 39|3@0+ (1,0) [0|7] ""  Dummy_FO
 SG_ FwdFusTrkB3LatPosDev : 36|3@0+ (1,0) [0|7] ""  Dummy_FO
 SG_ FwdFusTrkB3LngPosDev : 33|3@0+ (1,0) [0|7] ""  Dummy_FO

BU_: MRR
CM_ "AUTOGENERATED FILE, DO NOT EDIT";

CM_ "Imported file _comma.dbc starts here";
CM_ "gm_global_a_powertrain.dbc starts here";

CM_ BU_ K16_BECM "Battery Energy Control Module";
CM_ BU_ K73_TCIC "Telematics Communication Control Module";
CM_ BU_ K9_BCM "Body Control Module";
CM_ BU_ K43_PSCM "Power Steering Control Module";
CM_ BU_ K17_EBCM "Electronic Brake Control Module";
CM_ BU_ K20_ECM "Engine Control Module";
CM_ BU_ K114B_HPCM "Hybrid Powertrain Control Module";
CM_ BU_ NEO "Comma NEO";
CM_ BU_ K124_ASCM "Active Safety Control Module";
CM_ SG_ 352 ImmobilizerInfo "Non-zero when ignition or accessory mode";
CM_ SG_ 608 ClusterSpeed "Cluster speed signal seems to match dash on newer cars, but is a lower rate and can be noisier.";
BA_DEF_  "UseGMParameterIDs" INT 0 0;
BA_DEF_  "ProtocolType" STRING ;
BA_DEF_  "BusType" STRING ;
BA_DEF_DEF_  "UseGMParameterIDs" 1;
BA_DEF_DEF_  "ProtocolType" "GMLAN";
BA_DEF_DEF_  "BusType" "";
BA_ "BusType" "CAN";
BA_ "UseGMParameterIDs" 0;
VAL_ 1160 DgtlCommPncReset_B_Req 1 "Yes" 0 "No";
VAL_ 1160 DataMntrSustn_B_Rq 1 "Active" 0 "Inactive";
VAL_ 1160 PwSustnRdata_B_RqTelem 1 "Active" 0 "Inactive";
VAL_ 776 ScChrgrPwMax_Pw_RqCld 4095 "Faulty";
VAL_ 776 PrcondEdit_D_RqCld 7 "NotUsed_3" 6 "NotUsed_2" 5 "NotUsed_1" 4 "High" 3 "Medium" 2 "Low" 1 "Off" 0 "Null";
VAL_ 776 GoTEditMnte_T_RqCld 15 "Faulty" 14 "NoDataExists" 13 "NotUsed_2" 12 "NotUsed_1" 11 "Minute_55" 10 "Minute_50" 9 "Minute_45" 8 "Minute_40" 7 "Minute_35" 6 "Minute_30" 5 "Minute_25" 4 "Minute_20" 3 "Minute_15" 2 "Minute_10" 1 "Minute_5" 0 "Minute_0";
VAL_ 776 GoTEditHr_T_RqCld 31 "Faulty" 30 "NoDataExists";
VAL_ 776 ChrgToPcEdit_Pc_RqCld 127 "Faulty" 126 "NoDataExists";
VAL_ 776 ScFreshDataEnbl_B_Rq 1 "Yes" 0 "No";
VAL_ 776 ScEnbl_D_RqCld 3 "NotUsed" 2 "On" 1 "Off" 0 "Null";
VAL_ 774 ScLocLongPostv_B_RqCld 1 "Yes" 0 "No";
VAL_ 774 ScLocLattPostv_B_RqCld 1 "Yes" 0 "No";
VAL_ 774 ScLocDelete_B_RqCld 1 "Request" 0 "NoRequest";
VAL_ 868 BattRgenLoStat_D_Qlty 3 "OK" 2 "Not_Within_Spec" 1 "Eval_In_Progress" 0 "Faulty";
VAL_ 868 BattRgenLoPrtct_B_Stat 1 "Yes" 0 "No";
VAL_ 868 BattRgenLoDChrg_D_Stat 3 "StuckClosed" 2 "StuckOpen" 1 "Closed" 0 "Open";
VAL_ 868 BattRgenLoDchrg_B_Rq 1 "Yes" 0 "No";
VAL_ 868 BattRgenLoChrg_D_Stat 3 "StuckClosed" 2 "StuckOpen" 1 "Closed" 0 "Open";
VAL_ 868 BattRgenLoChrg_B_Rq 1 "Yes" 0 "No";
VAL_ 868 BattRgenLo_B_Falt 1 "Yes" 0 "No";
VAL_ 867 BattRgenLoBalnc_B_Rq 1 "Yes" 0 "No";
VAL_ 867 BattRgenLo_Te_Actl 255 "Fault";
VAL_ 865 BattRgenLo_U_Actl 2047 "Faulty";
VAL_ 865 BattRgenLo_I_Actl 65535 "Faulty";
VAL_ 1141 OfbChrgSetSync_D_Stat 3 "Fail" 2 "Success" 1 "InProgress" 0 "NoSyncInProgress";
VAL_ 1141 PtRmtRprt_D_Rq 15 "NotUsed_4" 14 "NotUsed_3" 13 "NotUsed_2" 12 "PlugInToMaintain12vBattery" 11 "SettingUpdated" 10 "FastChargeComplete" 9 "ChargeNotOccurring" 8 "OneTimeSocReached" 7 "BatteryTemperatureReminder" 6 "ReducedPerformance" 5 "LimitedPerformance" 4 "ChargeFault" 3 "ChargeComplete" 2 "VehiclePreconditioned" 1 "TripDistanceAchieved" 0 "NoReportRequest";
VAL_ 1141 NtfctnConflict1_D_Rq 7 "NotUsed5" 6 "NotUsed4" 5 "NotUsed3" 4 "NotUsed2" 3 "NotUsed1" 2 "Clonflict_Exists" 1 "No_Conflict" 0 "Invalid";
VAL_ 1140 RgenEvntLvl_Pc_Dsply 1023 "Fault" 1022 "NoDataExists";
VAL_ 1140 BrkEvntComplt_B_Dsply 1 "On" 0 "Off";
VAL_ 1140 PreCondStat_D_Dsply 7 "Reserved3" 6 "Reserved2" 5 "Reserved1" 4 "Faulted" 3 "Complete" 2 "In_Progress" 1 "Scheduled" 0 "Not_Scheduled";
VAL_ 1139 BattChrgTrgtLMax_T_Est 2047 "Faulty" 2046 "NoDataExists";
VAL_ 1139 ActChrgStrtYr_No_Actl 31 "Invalid";
VAL_ 1139 ActChrgStrtMin_No_Actl 63 "Invalid" 62 "Unknown";
VAL_ 1139 ActChrgStrtHr_No_Actl 31 "Invalid" 30 "Unknown";
VAL_ 1139 ActChrgStrtDay_No_Actl 31 "Invalid";
VAL_ 1139 ActChrgStrMnth_No_Actl 15 "Invalid";
VAL_ 1138 BattChrgTrgtLMin_T_Est 2047 "Faulty" 2046 "NoDataExists";
VAL_ 1138 ActChrgEndYr_No_Actl 31 "Invalid";
VAL_ 1138 ActChrgEndMnth_No_Actl 15 "Invalid";
VAL_ 1138 ActChrgEndMin_No_Actl 63 "Invalid" 62 "Unknown";
VAL_ 1138 ActChrgEndHr_No_Actl 31 "Invalid" 30 "Unknown";
VAL_ 1138 ActChrgEndDay_No_Actl 31 "Invalid";
VAL_ 1089 Mtr2Aout_W_ActlMntr 1023 "Faulty";
VAL_ 1089 Inv1_Te_Actl 255 "Faulty" 254 "NoDataExists";
VAL_ 1089 MtrTrac2Coil_Te_Actl 255 "Faulty" 254 "NoDataExists";
VAL_ 1089 MtrTrac2Falt_B_Stat 1 "Active" 0 "Inactive";
VAL_ 1089 MtrTrac2TeAlrm_B_Stat 1 "Active" 0 "Inactive";
VAL_ 1089 Mtr2CntlTeAlrm_B_Stat 1 "Active" 0 "Inactive";
VAL_ 1089 MtrTrac2Inv_Te_Actl 255 "Faulty" 254 "NoDataExists";
VAL_ 1089 MtrTrac2_I_Actl 65535 "Faulty";
VAL_ 1088 ChrgTMatch_B_Stat 1 "True" 0 "False";
VAL_ 1088 ChrgStat_D2_Dsply 15 "NotUsed_2" 14 "NotUsed_1" 13 "ChargeTargetReached" 12 "DriveConditioning" 11 "CabinPreconditioning" 10 "ChargingSystemMaintain" 9 "ChargingInductive" 8 "ChargingDCFastChange" 7 "ChargingAC" 6 "ChargeScheduled" 5 "EvsePaused" 4 "EvseNotDetected" 3 "EvseNotCompatible" 2 "FaultOutsideCar" 1 "FaultInsideCar" 0 "NotReady";
VAL_ 1088 HvacPrecondRecirc_D_Rq 3 "Last_User_Setting" 2 "Auto" 1 "Recirc" 0 "Outside";
VAL_ 1088 HvacPrecondMode2_D_Rq 15 "NotUsed4" 14 "NotUsed3" 13 "NotUsed2" 12 "NotUsed1" 11 "Last_User_Settings" 10 "Auto" 9 "Max_Defrost" 8 "Windshield_Panel_Floor" 7 "Windshield_Panel" 6 "Windshield" 5 "Windshield_Floor" 4 "Floor" 3 "Panel_Floor" 2 "Panel" 1 "MAX_AC" 0 "Off";
VAL_ 1088 HvacPrecondBlwr2_D_Rq 15 "NotUsed6" 14 "NotUsed5" 13 "NotUsed4" 12 "NotUsed3" 11 "NotUsed2" 10 "NotUsed1" 9 "Last_User_Setting" 8 "Auto" 7 "Speed7" 6 "Speed6" 5 "Speed5" 4 "Speed4" 3 "Speed3" 2 "Speed2" 1 "Speed1" 0 "Off";
VAL_ 1088 HvacPrecondAC_D_Rq 3 "Last_User_Setting" 2 "Auto" 1 "On" 0 "Off";
VAL_ 1088 BattChrgInhbt_D_Rq 3 "MaintainTargetSoc" 2 "NotUsed" 1 "InhibitChargingThermal" 0 "Enable_Charging";
VAL_ 871 BattElecPerf_D_Actl 7 "NotUsed" 6 "Hot_Batt_Severe_Lim_Perf" 5 "Hot_Batt_Reduced_Perf" 4 "Hot_Batt_Close_to_lim_Per" 3 "Cold_Batt_Severe_Lim_Perf" 2 "Cold_Batt_Reduced_Perf" 1 "Cold_Batt_Close_to_lim_Pe" 0 "Ok_no_message_displayed";
VAL_ 871 BattChrgTrgtLPt_T_Est 2047 "Faulty" 2046 "NoDataExists";
VAL_ 871 BattChrgTrgSocPt_T_Est 2047 "Faulty" 2046 "NoDataExists";
VAL_ 871 BattChrgCmpltPt_T_Est 2047 "Faulty" 2046 "NoDataExists";
VAL_ 1124 GPS_Vdop 31 "Invalid" 30 "Unknown";
VAL_ 1124 GPS_Speed 255 "Invalid" 254 "Unknown";
VAL_ 1124 GPS_Sat_num_in_view 31 "Invalid" 30 "Unknown";
VAL_ 1124 GPS_MSL_altitude 4095 "Fault" 4094 "Unknown";
VAL_ 1124 GPS_Heading 65535 "Fault" 65534 "Unknown";
VAL_ 1124 GPS_Hdop 31 "Invalid" 30 "Unknown";
VAL_ 1124 GPS_dimension 2 "_3D" 1 "_2D" 0 "No_Fix";
VAL_ 1123 GpsUtcYr_No_Actl 31 "Fault";
VAL_ 1123 GpsUtcMnth_No_Actl 15 "Fault";
VAL_ 1123 GPS_UTC_seconds 63 "Fault" 62 "Unknown";
VAL_ 1123 GPS_UTC_minutes 63 "Fault" 62 "Unknown";
VAL_ 1123 GPS_UTC_hours 31 "Invalid" 30 "Unknown";
VAL_ 1123 GPS_Pdop 31 "Invalid" 30 "Unknown";
VAL_ 1123 GPS_Compass_direction 7 "NorthWest" 6 "West" 5 "SouthWest" 4 "South" 3 "SouthEast" 2 "East" 1 "NorthEast" 0 "North";
VAL_ 1123 GPS_Actual_vs_Infer_pos 1 "Inferred_Position" 0 "Actual_Postition";
VAL_ 1123 Gps_B_Falt 1 "Yes" 0 "No";
VAL_ 1122 GpsHsphLongEast_D_Actl 0 "Invalid" 1 "Eastern" 2 "Western" 3 "Fault";
VAL_ 1122 GpsHsphLattSth_D_Actl 3 "Fault" 2 "Northern" 1 "Southern" 0 "Invalid";
VAL_ 1122 GPS_Longitude_Minutes 63 "Fault" 62 "Unknown";
VAL_ 1122 GPS_Longitude_Min_dec 16383 "Invalid" 16382 "Unknown";
VAL_ 1122 GPS_Longitude_Degrees 511 "Fault" 510 "Unknown";
VAL_ 1122 GPS_Latitude_Minutes 63 "Fault" 62 "Unknown";
VAL_ 1122 GPS_Latitude_Min_dec 16383 "Invalid" 16382 "Unknown";
VAL_ 1122 GPS_Latitude_Degrees 255 "Invalid" 254 "Unknown";
VAL_ 1186 SelDrvMdeAwd2_D_Stat 31 "Faulty" 30 "NotUsed_17" 29 "NotUsed_16" 28 "NotUsed_15" 27 "NotUsed_14" 26 "NotUsed_13" 25 "NotUsed_12" 24 "NotUsed_11" 23 "NotUsed_10" 22 "NotUsed_9" 21 "NotUsed_8" 20 "NotUsed_7" 19 "NotUsed_6" 18 "NotUsed_5" 17 "EvLaterChargeMode" 16 "EvNowMode" 15 "TrackMode" 14 "RoughRoadMode" 13 "NotAvailable" 12 "HighSpeedDesertMode_Baja" 11 "SportAdaptiveMode" 10 "RockCrawlMode" 9 "MudRutsMode" 8 "SandMode" 7 "EconomyMode" 6 "GrassGravelSnow" 5 "TowHaulMode" 4 "SportMode" 3 "Normal_4L" 2 "Normal_4A" 1 "Normal_2H" 0 "NormalMode";
VAL_ 1186 RearDiffLckMsg_D_Rq 7 "Locker_Disabled" 6 "Locker_Enabled" 5 "Locker_Accel_Pedal" 4 "Speed4" 3 "Speed3" 2 "Spee2" 1 "Speed1" 0 "Normal__No_Message ";
VAL_ 1186 RearDiffLckLamp_D_Rq 3 "Not_Used" 2 "Flash" 1 "On" 0 "Off";
VAL_ 1186 RearDiffLck_Tq_Actl 4095 "Fault" 4094 "Unknown";
VAL_ 1186 RearDiffFalt_D_Stat 3 "Diff_Failed_Closed" 2 "Diff_Failed_Open" 1 "Fault_Non_Specific" 0 "No_Fault";
VAL_ 1186 LsdSrvcRqd_B_Rq 1 "On" 0 "Off";
VAL_ 611 AwdSys_D_Stat 3 "Faulty" 2 "NotUsed" 1 "_4x4_L_H_Active" 0 "_4x4_L_H_Inactive";
VAL_ 611 AwdStat_D_RqDsply 31 "NotUsed9" 30 "NotUsed8" 29 "NotUsed7" 28 "To_Engage_4x4_Release_Aped" 27 "To_Engage_4x4_Slow_To_3MPH" 26 "Shift_To_Neutral" 25 "Lkr_Mode_Unavail_TMS" 24 " _4x4_Mode_Unavail_TMS" 23 "Out_of_4Low_Crawl" 22 "AWD_PTU_Oil_Changed" 21 "Change_AWD_PTU_Oil" 20 "Neutral_Tow_Disabled" 19 "Neutral_Tow_Enabled" 18 "AWD_OFF" 17 "_4x4_Off_Road_Speed" 16 "_4x4_Extreme_Off_Road_Mode" 15 "_4x4_Exiting_Off_Road" 14 "_4x4_Off_Road_Mode" 10 "_4x4_Locked_Temporarily" 9 "Shift_In_Progress" 13 "Blocked_Shift_Assist" 12 "_4x4_Auto_Restored" 11 "_4x4_Disabled_Temporarily" 7 "Out_of_4Low__Neutral" 6 "Out_of_4Low__Brake" 5 "Out_of_4Low__Speed" 4 "Into_4Low__Clutch" 3 "Into_4Low__Neutral" 2 "Into_4Low__Brake" 1 "Into_4Low__Speed" 0 "Normal__No_Message" 8 "Out_of_4Low__Clutch";
VAL_ 611 AwdLck_D_Stat 9 "Undefined" 8 "Under_External_Torque_Ctrl" 7 "Torque_Limited_by_Cmd" 6 "Fully_Locked_by_Cmd" 5 "Disabled" 4 "Warning" 3 "Fault" 2 "Inactive" 1 "Completely_Opened_by_Cmd" 0 "OK";
VAL_ 611 AwdSrvcRqd_B_Rq 1 "On" 0 "Off";
VAL_ 611 NtrlTowAvail_B_Stat 1 "Available" 0 "NotAvailable";
VAL_ 611 AwdLck_Tq_Rq 4095 "Fault" 4094 "Unknown";
VAL_ 611 AwdOffRoadMode_D_Stats 3 "Invalid" 2 "Extreme_Off_Road" 1 "Off_Road" 0 "Normal_Mode";
VAL_ 611 AwdLoLamp_D_RqDsply 3 "Not_Used" 2 "Flash" 1 "On" 0 "Off";
VAL_ 611 AwdHiLamp_D_RqDsply 3 "Not_Used" 2 "Flash" 1 "On" 0 "Off";
VAL_ 611 AwdAutoLamp_D_RqDsply 3 "Not_Used" 2 "Flash" 1 "On" 0 "Off";
VAL_ 611 Awd2wdLamp_D_RqDsply 3 "Not_Used" 2 "Flash" 1 "On" 0 "Off";
VAL_ 611 AwdRnge_D_Actl 7 "Unknown" 6 "High_Range_2wd" 5 "High_Range_Auto" 4 "High_Range_Locked" 3 "Neutral" 2 "Low_Range_2wd" 1 "Low_Range_Auto" 0 "Low_Range_Locked";
VAL_ 1056 AutoEpbMsgTxt_D_Rq 7 "Message7" 6 "Message6" 5 "Message5" 4 "Message4" 3 "Message3" 2 "Message2" 1 "Message1" 0 "NoMessage";
VAL_ 1056 AutoEpbDsply_D_Stat 1 "Available" 0 "NotAvailable";
VAL_ 1056 AutoEpbButtnOn_B_Stat 1 "On" 0 "Off";
VAL_ 1056 SelDrvMdePos12_B_Avail 1 "Available" 0 "NotAvailable";
VAL_ 1056 SelDrvMdePos11_B_Avail 1 "Available" 0 "NotAvailable";
VAL_ 1056 SelDrvMdePos10_B_Avail 1 "Available" 0 "NotAvailable";
VAL_ 1056 SelDrvMdePos09_B_Avail 1 "Available" 0 "NotAvailable";
VAL_ 1056 SelDrvMdePos08_B_Avail 1 "Available" 0 "NotAvailable";
VAL_ 1056 SelDrvMdePos07_B_Avail 1 "Available" 0 "NotAvailable";
VAL_ 1056 SelDrvMdePos06_B_Avail 1 "Available" 0 "NotAvailable";
VAL_ 1056 SelDrvMdePos05_B_Avail 1 "Available" 0 "NotAvailable";
VAL_ 1056 SelDrvMdePos04_B_Avail 1 "Available" 0 "NotAvailable";
VAL_ 1056 SelDrvMdePos03_B_Avail 1 "Available" 0 "NotAvailable";
VAL_ 1056 SelDrvMdePos02_B_Avail 1 "Available" 0 "NotAvailable";
VAL_ 1056 SelDrvMdePos01_B_Avail 1 "Available" 0 "NotAvailable";
VAL_ 1056 ActvDrvMde_D2_Stat 31 "Faulty" 30 "SelDrvMde31" 29 "SelDrvMde30" 28 "SelDrvMde29" 27 "SelDrvMde28" 26 "SelDrvMde27" 25 "SelDrvMde26" 24 "SelDrvMde25" 23 "SelDrvMde24" 22 "SelDrvMde23" 21 "SelDrvMde22" 20 "SelDrvMde21" 19 "SelDrvMde20" 18 "SelDrvMde19" 17 "SelDrvMde18" 16 "SelDrvMde17" 15 "SelDrvMde16" 14 "SelDrvMde15" 13 "SelDrvMde14" 12 "SelDrvMde13" 11 "SelDrvMde12" 10 "SelDrvMde11" 9 "SelDrvMde10" 8 "SelDrvMde09" 7 "SelDrvMde08" 6 "SelDrvMde07" 5 "SelDrvMde06" 4 "SelDrvMde05" 3 "SelDrvMde04" 2 "SelDrvMde03" 1 "SelDrvMde02" 0 "SelDrvMde01";
VAL_ 1056 SelDrvMde_D2_Rq 31 "Faulty" 30 "SelDrvMde31" 29 "SelDrvMde30" 28 "SelDrvMde29" 27 "SelDrvMde28" 26 "SelDrvMde27" 25 "SelDrvMde26" 24 "SelDrvMde25" 23 "SelDrvMde24" 22 "SelDrvMde23" 21 "SelDrvMde22" 20 "SelDrvMde21" 19 "SelDrvMde20" 18 "SelDrvMde19" 17 "SelDrvMde18" 16 "SelDrvMde17" 15 "SelDrvMde16" 14 "SelDrvMde15" 13 "SelDrvMde14" 12 "SelDrvMde13" 11 "SelDrvMde12" 10 "SelDrvMde11" 9 "SelDrvMde10" 8 "SelDrvMde09" 7 "SelDrvMde08" 6 "SelDrvMde07" 5 "SelDrvMde06" 4 "SelDrvMde05" 3 "SelDrvMde04" 2 "SelDrvMde03" 1 "SelDrvMde02" 0 "SelDrvMde01";
VAL_ 1056 SelDrvMdePt_D_Rq 31 "Faulty" 30 "NotUsed15" 29 "NotUsed14" 28 "NotUsed13" 27 "NotUsed12" 26 "NotUsed11" 25 "NotUsed10" 24 "NotUsed9" 23 "NotUsed8" 22 "NotUsed7" 21 "NotUsed6" 20 "NotUsed5" 19 "NotUsed4" 18 "EvLaterChargerMode" 17 "EvNowMode" 16 "DragMode" 15 "HighSpeedDesertMode_Baja" 14 "SportAdaptiveMode" 13 "NotAvailable_13" 12 "NotAvailable_12" 11 "NotAvailable_11" 10 "NotAvailable_10" 9 "RockCrawlMode" 8 "MudRutsMode" 7 "SandMode" 6 "EconomyMode" 5 "GrassGravelSnow" 4 "NotAvailable_04" 3 "TowHaulMode" 2 "NotAvailable_02" 1 "SportMode" 0 "NormalMode";
VAL_ 1056 SelDrvMdeMsgTxt_D_Rq 15 "Message15" 14 "Message14" 13 "Message13" 12 "Message12" 11 "Message11" 10 "Message10" 9 "Message9" 8 "Message8" 7 "Message7" 6 "Message6" 5 "Message5" 4 "Message4" 3 "Message3" 2 "Message2" 1 "Message1" 0 "NoMessage";
VAL_ 1056 SelDrvMde_D_Stat 3 "NotUsed" 2 "DriveModeChangeRequest" 1 "DriveModeChangeSelection" 0 "NoDriveModeChangeRequest";
VAL_ 1056 AwdMde_D_RqBrk 7 "Faulty" 6 "NotUsed2" 5 "NoRequest" 4 "Neutral" 3 "FourByFourLow" 2 "FourByFourHigh" 1 "FourByFourAuto" 0 "FourByTwo";
VAL_ 1090 Mtr2State_D_ActlMntr 7 "Faulty" 6 "NoDataExists" 5 "NotUsed_1" 4 "ReadinessState" 3 "DeactivationState" 2 "PowerGeneration" 1 "PowerConsumption" 0 "Null";
VAL_ 1090 Inv1Ain_I_ActlMntr 32767 "Faulty" 32766 "NoDataExists";
VAL_ 1090 HybVehMde_D_ActlMntr 7 "Faulty" 6 "NoDataExists" 5 "NotUsed_2" 4 "NotUsed_1" 3 "Fuel" 2 "HybridElectric" 1 "AllElectric" 0 "Null";
VAL_ 1090 ChrgStat_D_ActlMntr 7 "Faulty" 6 "NoDataExists" 5 "NotUsed" 4 "ChargingCompleted" 3 "NotCharging" 2 "ChargingInDrivingState" 1 "ChargingInParkingState" 0 "Null";
VAL_ 1090 VehElRnge_L_Dsply 4094 "NoDataExists" 4095 "Fault";
VAL_ 870 EngMdeMsgTxt_D_Rq 7 "NotUsed_3" 6 "NotUsed_2" 5 "NotUsed_1" 4 "Charge" 3 "GlowingCharge" 2 "Hybrid" 1 "Ev" 0 "NoMessage";
VAL_ 870 RngPerChrgInst_L_Dsply 4095 "Faulty" 4094 "NoDataExists";
VAL_ 869 PwrFlowTxt_D_Dsply 15 "NotUsed7" 14 "NotUsed6" 13 "NotUsed5" 12 "NotUsed4" 11 "Disply_Rgen_Chrg_Txt" 10 "Disp_Fast_Charge_Txt" 9 "Disp_Fast_Charge_Cmplt_Txt" 8 "Disp_Charge_Cmplt_Txt" 7 "Disp_Remote_Start_Txt" 6 "Disp_Eng_Drv_Txt" 5 "Disp_Elec_Drv_Txt" 4 "Disp_Idle_with_Chrg_Txt" 3 "Disp_Idle_Txt" 2 "Disp_Charg_HV_Batt_Txt" 1 "Disp_Hyb_Drive_Txt" 0 "No_Text";
VAL_ 869 EngOnMsg2_D_Dsply 14 "_0xE_to_1F_NotUsed" 12 "Battery_Temperature" 11 "Hill_Decent_Control" 10 "Fuel_Maintenance" 9 "Oil_Maintenance" 8 "Normal_Operation" 7 "Low_Gear" 6 "Batt_Charging" 5 "Engine_Cold" 4 "Neutral_Gear" 3 "Heater_Setting" 2 "High_Speed" 1 "Acceleration" 0 "No_Display" 13 "Drive_Mode_Selection";
VAL_ 869 EngOnMsg1_D_Dsply 14 "_0xE_to_1F_NotUsed" 12 "Battery_Temperature" 11 "Hill_Decent_Control" 10 "Fuel_Maintenance" 9 "Oil_Maintenance" 8 "Normal_Operation" 7 "Low_Gear" 6 "Batt_Charging" 5 "Engine_Cold" 4 "Neutral_Gear" 3 "Heater_Setting" 2 "High_Speed" 1 "Acceleration" 0 "No_Display" 13 "Drive_Mode_Selection";
VAL_ 869 FuelMaintMde_D_Dsply 3 "Feature_Not_Present" 2 "In_Fuel_Maint_Mode" 1 "Close_to_Fuel_Maint" 0 "OK";
VAL_ 869 EngActv_B_Dsply 1 "On" 0 "Off";
VAL_ 869 EffWhlThresOn_B_Dsply 1 "On" 0 "Off";
VAL_ 606 ElVehLaterMde_D_Stat 3 "NotUsed" 2 "Available" 1 "NotAvailable" 0 "Null";
VAL_ 606 ElVehNowMde_D_Stat 3 "NotUsed" 2 "Available" 1 "NotAvailable" 0 "Null";
VAL_ 602 HtrnWarnLamp_B_Dsply 1 "On" 0 "Off";
VAL_ 602 HybPwLimOn_B_Stat 1 "Yes" 0 "No";
VAL_ 602 PwPckTqRdy_B_Dsply 1 "On" 0 "Off";
VAL_ 1100 EngExhMdeQuiet_D2_Stat 7 "Faulty" 6 "NotUsed_2" 5 "NotUsed_1" 4 "Track" 3 "Sport" 2 "Normal" 1 "Stealth" 0 "Null";
VAL_ 1100 HvacCmprLim_D_Stat 7 "NotUsed_2" 6 "NotUsed_1" 5 "CompressorHeadPressure" 4 "AvailableTorque" 3 "PedalPosition" 2 "RPM" 1 "ECT" 0 "NoLimit";
VAL_ 1100 WakeAlarm1_B_Typ 1 "CanAndEcuDriveCircuit" 0 "CanOnly";
VAL_ 1100 Veh_V_DsplyTrailCtlSet 63 "Faulty";
VAL_ 1100 TrailCtlPt_B_Falt 1 "Fault" 0 "No_Fault";
VAL_ 1100 AutoTowAllw_D_StatMnu 3 "TowHaulCommandedOn" 2 "AutoTowHaulEnabled" 1 "AutoTowHaulDisabled" 0 "NoSelection";
VAL_ 1100 AutoTowActv_B_Stat 1 "Yes" 0 "No";
VAL_ 1100 GrossTrainWeight_M_Est 255 "Faulty" 254 "NoDataExists";
VAL_ 1098 EdmSailMdeOn_B_Stat 1 "On" 0 "Off";
VAL_ 1098 EdmMsgTxt_D_Rq 15 "NotUsed_4" 14 "NotUsed_3" 13 "NotUsed_2" 12 "NotUsed_1" 11 "OverallGoodScore" 10 "WorkOnCompliance" 9 "GoodCompliance" 8 "WorkOnGearShifting" 7 "GoodGearShifting" 6 "WorkOnEfficientSpeed" 5 "GoodEfficientSpeed" 4 "WorkOnDeceleration" 3 "GoodDeceleration" 2 "WorkOnAcceleration" 1 "GoodAcceleration" 0 "NoMessage";
VAL_ 1098 EdmLamp_D_Dsply 15 "NotUsed_7" 14 "NotUsed_6" 13 "NotUsed_5" 12 "NotUsed_4" 11 "NotUsed_3" 10 "NotUsed_2" 9 "NotUsed_1" 8 "CoastingEngineBrake" 7 "CoastingShiftToNeutral" 6 "FreewayJunction" 5 "Curve2" 4 "Curve1" 3 "SpeedLimit" 2 "Crossing" 1 "FreewayExit" 0 "NoRecommendation";
VAL_ 1098 EdmCmplnc_B_Dsply 1 "Yes" 0 "No";
VAL_ 1060 RearDiffOilTeWarn_B_Rq 1 "On" 0 "Off";
VAL_ 1060 RearDiffOil_Te_Actl 511 "Faulty";
VAL_ 1060 BpedDrvMsgTxt_B_Dsply 1 "On" 0 "Off";
VAL_ 1060 FuelLvlWarn_D_ActlEng 7 "DteLevel5Lowest" 6 "DteLevel4" 5 "DteLevel3" 4 "DteLevel2NonMyKey" 3 "DteLevel1MyKey" 2 "VeryLow" 1 "Low" 0 "OK";
VAL_ 1060 SelDrvMdePt_D_Stat 0 "NotAvailable" 1 "Available" 2 "TemporarilyNotAvailable" 3 "Faulty";
VAL_ 1057 FohEng_D_Rq 3 "AutoEnable_ParkEnable" 2 "AutoDisable_ParkEnable" 1 "AutoEnable_ParkDisable" 0 "Disable_Stop";
VAL_ 1057 EngIdlShutDwnTxt_D_Rq 3 "NotUsed" 2 "EngineShutdownOnPrevDrive" 1 "FeatureDisabledDueToFault" 0 "NoMessage";
VAL_ 1057 EngIdlShutDown_D_Stat 3 "Not_used" 2 "Engine_Shutdown" 1 "Initiated_Countdown" 0 "Normal_Operation";
VAL_ 1057 FUEL_ALCOHOL_PERCNT 255 "Invalid";
VAL_ 1057 TrnTotTq_Rt_Est 65535 "Fault" 65534 "Unknown";
VAL_ 1057 TrnTotLss_Tq_Est 255 "Fault" 254 "Unknown";
VAL_ 1057 ECMMILRequest 3 "Not_Used" 2 "Flash" 1 "On" 0 "Off";
VAL_ 1057 AirCondFluidHi_P_Actl 255 "Fault" 254 "Unknown";
VAL_ 1057 OilPressureWarning 1 "Low_Pressure_Lamp_On" 0 "Normal_Pressure_Lamp_Off";
VAL_ 1057 VehVLimStat_D_Actl 7 "Undefined_3" 6 "Undefined_2" 5 "Undefined_1" 4 "ASL_Fault_Condition" 3 "Active_and_Limiting" 2 "Active_but_Not_Limiting" 1 "Standby" 0 "Off";
VAL_ 1057 VehVLimActv_B_Actl 1 "Active" 0 "Inactive";
VAL_ 1057 CoolantFanStepAct 31 "Unused7" 30 "Unused6" 29 "Unused5" 28 "Unused4" 27 "Unused3" 26 "Unused2" 25 "Unused1" 23 "Step23" 22 "Step22" 21 "Step21" 20 "Step20" 19 "Step19" 18 "Step18" 17 "Step17" 16 "Step16" 15 "Step15" 14 "Step14" 13 "Step13" 12 "Step12" 11 "Step11" 10 "Step10" 9 "Step9" 8 "Step8" 7 "Step7" 6 "Step6" 5 "Step5" 4 "Step4" 3 "Step3" 2 "Step2" 1 "Step1" 24 "Max_Fan_Speed_Req" 0 "Fan_Cmd_Off";
VAL_ 1067 BattULoAuxIsol_D_Rq 3 "Undefined" 2 "Retain" 1 "Close" 0 "Open";
VAL_ 1067 BattULoAux_U_Rq 4095 "Faulty";
VAL_ 1067 BattULoAux_I_Actl 4095 "Faulty";
VAL_ 1067 BattULoAux_D_Qlty 3 "OK" 2 "Not_Within_Specifications" 1 "Eval_In_Progress" 0 "Faulty";
VAL_ 1067 BattULoAux_U_Actl 255 "Faulty";
VAL_ 1067 BattULoAux_B_Falt 1 "Fault" 0 "No_Fault";
VAL_ 1121 SelDrvMdeSwtch_D_Stat 3 "Faulty" 2 "SwitchState2" 1 "SwitchState1" 0 "NotPressed";
VAL_ 1121 SelDrvMdeCnt_D_Stat 4 "FourCounts" 3 "ThreeCounts" 2 "TwoCounts" 1 "OneCount" 0 "ZeroCounts" 7 "SevenOrMoreCounts" 6 "SixCounts" 5 "FiveCounts";
VAL_ 1120 DrvSlipCtlMde_B_Rq3 1 "Pressed" 0 "Not_Pressed";
VAL_ 1120 HybMdeSwtch_B_Rq 1 "Pressed" 0 "Not_Pressed";
VAL_ 1120 TrailCtlSwtch_B_Stat3 1 "Pressed" 0 "Not_Pressed";
VAL_ 1120 RearDiffLck_D_RqDrv 3 "Faulty" 2 "NoRequest" 1 "On" 0 "Off";
VAL_ 1120 AwdMde_D_RqDrv 7 "Faulty" 6 "NotUsed2" 5 "NoRequest" 4 "Neutral" 3 "FourByFourLow" 2 "FourByFourHigh" 1 "FourByFourAuto" 0 "FourByTwo";
VAL_ 1120 HdcSwtchPos_B_Actl 1 "Pressed" 0 "Not_Pressed";
VAL_ 1137 RngPerChrgAvg_L_Dsply 4095 "Faulty" 4094 "NoDataExists";
VAL_ 588 BattTracSoc2_Pc_Actl 16383 "Faulty" 16382 "NoDataExists";
VAL_ 588 BattTrac_Te_Actl 1023 "Fault" 1022 "Unknown";
VAL_ 588 BattTracDiagClr_B_Rq 1 "On" 0 "Off";
VAL_ 587 BattTracWarnLamp_B_Rq 1 "On" 0 "Off";
VAL_ 587 BattTracSrvcRqd_B_Rq 1 "On" 0 "Off";
VAL_ 1091 ParkLampTrlrOut_B_Stat 1 "Out" 0 "Null";
VAL_ 1091 TrlrLampCtl_D_Stat 3 "NotUsed" 2 "TrlrLampCnnctDrvFailure" 1 "TrlrLampNotCnnctDrvFailure" 0 "Null";
VAL_ 1091 TrlrBattChrg_D_Stat 3 "Reverse" 2 "Normal" 1 "Low" 0 "Null";
VAL_ 1091 StopLampTrlrOut_B_Stat 1 "Out" 0 "Null";
VAL_ 1091 TurnLampTrlrRr_B_Stat 1 "Out" 0 "Null";
VAL_ 1091 TurnLampTrlrRl_B_Stat 1 "Out" 0 "Null";
VAL_ 1091 TrlrLampCnnct_B_Actl 1 "Yes" 0 "No";
VAL_ 1093 TrlBrkInitOut_D_Stat 3 "Heavy" 2 "Medium" 1 "Light" 0 "Null";
VAL_ 1093 TrlrBrkMde_D_Actl 1 "Electric_Over_Hydraulic" 0 "Electric";
VAL_ 1093 TrlrBrkDsply_B_Rq 1 "Yes" 0 "No";
VAL_ 1093 TrlrBrkDcnnt_B_Actl 1 "Yes" 0 "No";
VAL_ 1093 TrlrBrkActCnnct_B_Actl 1 "Yes" 0 "No";
VAL_ 1093 StopLamp_B_RqTrlrBrk 1 "Yes" 0 "No";
VAL_ 1093 TrlrBrkCtl_B_Falt 1 "Yes" 0 "No";
VAL_ 1093 TrlrBrkActCirct_B_Falt 1 "Yes" 0 "No";
VAL_ 862 AutoStpHvacDelta_I_Est 255 "Fault";
VAL_ 862 HvacBlwrFront_D_Stat 31 "Not_Used" 20 "Full_On" 19 "95_Percent" 18 "90_Percent" 17 "85_Percent" 16 "80_Percent" 15 "75_Percent" 14 "70_Percent" 13 "65_Percent" 12 "60_Percent" 11 "55_Percent" 10 "50_Percent" 9 "45_Percent" 8 "40_Percent" 7 "35_Percent" 6 "30_Percent" 5 "25_Percent" 4 "20_Percent" 3 "15_Percent" 2 "10_Percent" 1 "5_Percent" 0 "Off";
VAL_ 862 CabnAmb_Te_Actl 255 "Fault";
VAL_ 862 ClimtThrmlLoad_No_Actl 255 "Fault";
VAL_ 578 PtLatchActv_B_RqBcm 1 "On" 0 "Off";
VAL_ 578 immoSecureIdleMode 3 "NotUsed2" 2 "NotUsed1" 1 "Active" 0 "Inactive";
VAL_ 578 ReFuelSwtchStat_D_Actl 3 "NotUsed2" 2 "NotUsed1" 1 "On" 0 "Off";
VAL_ 578 FuelPumpPwr_D_Stat 7 "NotUsed3" 6 "NotUsed2" 5 "NotUsed1" 4 "Power_Off_Default" 3 "Power_Off_Command" 2 "Power_Off_Service" 1 "Power_Off_Impact" 0 "Power_On";
VAL_ 578 BattULo_U_Actl 255 "Fault";
VAL_ 578 PrkLckCtl_B_Enbl 1 "Enable" 0 "Disable";
VAL_ 578 PrkLckCtlMsgTxt_D_Rq 3 "BTSI_DI_3" 2 "BTSI_DI_2" 1 "BTSI_DI_1" 0 "Null_BTSI_DI";
VAL_ 578 BrkTrnShifLck_B_Stat 1 "Shift" 0 "NoShift";
VAL_ 578 PrkLckCtlUnlck_D_Stat 3 "Trans_And_Steer_Unlckd" 2 "Steering_Unlckd" 1 "Transmission_Unlckd" 0 "Null";
VAL_ 578 PrkLckCtlTow_B_Enbl 1 "Enable" 0 "Disable";
VAL_ 578 DriverCrankingReq 1 "Crank_Request" 0 "No_Crank_Request";
VAL_ 578 EngOff_T_Actl 65535 "Invalid";
VAL_ 578 DcacElPw_D_Rq 3 "NotUsed" 2 "AC_HighPower_Requested" 1 "AC_LowPower_Requested" 0 "AC_Power_NotRequested";
VAL_ 578 BattULo_I_Actl 16383 "Fault";
VAL_ 1068 EngStrtInhbt_B_RqBatt 1 "Start_Inhibit" 0 "Dont_Care";
VAL_ 1068 BattULoChrg_D_Rq 3 "Low_Battery_Temperature" 2 "Charging_Requested" 1 "Chrg_Requested_HighCurrent" 0 "No_Request";
VAL_ 1068 PwSysULoFalt_D_Stat 15 "Not_Used_6" 14 "LowBatterySOC" 13 "PSS_Shed2_Contin" 12 "Not_Used_4" 11 "Not_Used_3" 10 "Not_Used_2" 9 "BattMonitoringSensorFault" 8 "LowBattVoltDuringPwSrcOn" 7 "LowBatt2_PowerSaveMode" 6 "LowBatt1_Warning" 5 "Overvoltage" 4 "Fault_NoOutput" 3 "Fault_ReducedOutput" 2 "Fault_Nonspecific" 1 "Cluster_Proveout" 0 "No_Fault";
VAL_ 1068 Shed_T_Eng_Off_B 1 "Active" 0 "Inactive";
VAL_ 1068 Shed_Feature_Group_ID 16 "PtcHeater" 14 "HtdMirr" 13 "HvacRearBlwr_Third" 12 "HvacRearBlwr_Second" 11 "HvacRearBlwr_First" 31 "All LSHED1 Features" 10 "Htd_Windscrn" 9 "SpltHtdBcklight_HtdMirr" 8 "HtdBcklight_HtdMirr" 7 "HtdCoolSeat_FrtDriver" 6 "HtdCoolSeat_FrtPass" 5 "HtdCoolSeat_RearPass" 4 "HtdCoolSeat_RearDriver" 3 "SmartTrlrTowBattCharge" 2 "Htd_StrWhl" 1 "Htd_Washer_Fluid" 0 "No_LSHED1_Features" 15 "Engine_Coolant_Fan";
VAL_ 1068 Shed_Drain_Eng_Off_B 1 "Active" 0 "Inactive";
VAL_ 1068 Shed_Level_Req 7 "Unused_2" 6 "Loads_On" 5 "SHED_ENG_OFF" 4 "SOON_ENG_OFF" 3 "SHED2_CONTIN" 2 "SHED2_TRANS" 1 "SHED1" 0 "NO_SHED";
VAL_ 1068 ULoRgenTestMde_B_Rq 1 "Request" 0 "NoRequest";
VAL_ 1068 ChargeMode 7 "Undefined_2" 6 "Undefined_1" 5 "Battery_Identify" 4 "Battery_Refresh" 3 "SlowRegenAllowNoDischarge" 2 "Fast_Regen_Allowed" 1 "Slow_Regen_Allowed" 0 "Conventional_Charging";
VAL_ 1068 IdleSpeedIncrease_El 1 "Yes" 0 "No";
VAL_ 1068 Batt_Lo_SoC_B 1 "Active" 0 "Inactive";
VAL_ 1068 PeriodicElLoad_B_Stat 1 "Active" 0 "Inactive";
VAL_ 1068 Batt_Crit_SoC_B 1 "Active" 0 "Inactive";
